VERSION ""

NS_ :

BS_:

BU_: DKY PSC MCR MCL PRG SRM AHL SMT TPM ACN EAM_HUD DAM BIU C_ECU C_ECU_GW

BO_ 1510 EAM5E6: 8 Vector__XXX

BO_ 1511 EAM5E7: 8 EAM_HUD
 SG_ EAM5E7_7_0_DATA : 7|64@0+ (1,0) [0|1.844674407371E+19] "" Vector__XXX

BO_ 552 RDR228: 8 C_ECU_GW
 SG_ RDR228_7_0_EYE_TIMEOUT_ERROR_FLG : 56|1@1+ (1,0) [0|1] "" Vector__XXX
 SG_ RDR228_7_1_BLOCKAGE_FORMING_2 : 57|1@1+ (1,0) [0|1] "" Vector__XXX
 SG_ RDR228_7_2_WARN_LCA_R_1ST : 58|1@1+ (1,0) [0|1] "" Vector__XXX
 SG_ RDR228_7_3_WARN_LCA_L_1ST : 59|1@1+ (1,0) [0|1] "" Vector__XXX
 SG_ RDR228_7_4_WARN_LCA_R_2ND : 60|1@1+ (1,0) [0|1] "" Vector__XXX
 SG_ RDR228_7_5_WARN_LCA_L_2ND : 61|1@1+ (1,0) [0|1] "" Vector__XXX
 SG_ RDR228_7_6_WARN_RCTA_R : 62|1@1+ (1,0) [0|1] "" Vector__XXX
 SG_ RDR228_7_7_WARN_RCTA_L : 63|1@1+ (1,0) [0|1] "" Vector__XXX
 SG_ RDR228_6_0_WARN_BSD_R_1ST : 48|1@1+ (1,0) [0|1] "" Vector__XXX
 SG_ RDR228_6_1_WARN_BSD_L_1ST : 49|1@1+ (1,0) [0|1] "" Vector__XXX
 SG_ RDR228_6_2_WARN_BSD_R_2ND : 50|1@1+ (1,0) [0|1] "" Vector__XXX
 SG_ RDR228_6_3_WARN_BSD_L_2ND : 51|1@1+ (1,0) [0|1] "" Vector__XXX
 SG_ RDR228_6_5_BLOCKAGE_STS : 53|3@1+ (1,0) [0|5] "" Vector__XXX
 SG_ RDR228_5_0_BSD_R_E : 40|1@1+ (1,0) [0|1] "" Vector__XXX
 SG_ RDR228_5_1_BSD_L_E : 41|1@1+ (1,0) [0|1] "" Vector__XXX
 SG_ RDR228_5_2_LCA_R_E : 42|1@1+ (1,0) [0|1] "" Vector__XXX
 SG_ RDR228_5_3_LCA_L_E : 43|1@1+ (1,0) [0|1] "" Vector__XXX
 SG_ RDR228_5_4_BSD_R_A : 44|1@1+ (1,0) [0|1] "" Vector__XXX
 SG_ RDR228_5_5_BSD_L_A : 45|1@1+ (1,0) [0|1] "" Vector__XXX
 SG_ RDR228_5_6_LCA_R_A : 46|1@1+ (1,0) [0|1] "" Vector__XXX
 SG_ RDR228_5_7_LCA_L_A : 47|1@1+ (1,0) [0|1] "" Vector__XXX
 SG_ RDR228_4_0_DOW_ACTIVELAMP : 32|1@1+ (1,0) [0|1] "" Vector__XXX
 SG_ RDR228_4_1_WARN_DOW_1ST_R : 33|1@1+ (1,0) [0|1] "" Vector__XXX
 SG_ RDR228_4_2_WARN_DOW_1ST_L : 34|1@1+ (1,0) [0|1] "" Vector__XXX
 SG_ RDR228_4_3_WARN_DOW_2ST_R : 35|1@1+ (1,0) [0|1] "" Vector__XXX
 SG_ RDR228_4_4_WARN_DOW_2ST_L : 36|1@1+ (1,0) [0|1] "" Vector__XXX
 SG_ RDR228_4_5_CSTM_STS_SRVD : 37|1@1+ (1,0) [0|1] "" Vector__XXX
 SG_ RDR228_4_6_CSTM_STS_BSD_LCA_2ND : 38|1@1+ (1,0) [0|1] "" Vector__XXX
 SG_ RDR228_4_7_CSTM_STS_RCTA : 39|1@1+ (1,0) [0|1] "" Vector__XXX
 SG_ RDR228_3_0_WARN_BSD_LCA_R_2ND : 24|1@1+ (1,0) [0|1] "" Vector__XXX
 SG_ RDR228_3_1_WARN_BSD_LCA_L_2ND : 25|1@1+ (1,0) [0|1] "" Vector__XXX
 SG_ RDR228_3_2_CSTM_STS_DOW : 26|1@1+ (1,0) [0|1] "" Vector__XXX
 SG_ RDR228_3_3_CSTM_STS_DOW_SFT_POS : 27|1@1+ (1,0) [0|1] "" Vector__XXX
 SG_ RDR228_3_5_CSTM_DSP_BSD_LCA : 29|1@1+ (1,0) [0|1] "" Vector__XXX
 SG_ RDR228_3_6_CSTM_DSP_BSD_LCA_2ND : 30|1@1+ (1,0) [0|1] "" Vector__XXX
 SG_ RDR228_3_7_CSTM_DSP_RCTA : 31|1@1+ (1,0) [0|1] "" Vector__XXX
 SG_ RDR228_2_0_CSTM_DSP_DOW : 16|1@1+ (1,0) [0|1] "" Vector__XXX
 SG_ RDR228_2_1_EYE_LOCAL_BUS1_FAIL : 17|1@1+ (1,0) [0|1] "" Vector__XXX
 SG_ RDR228_2_2_CSTM_DSP_DOW_SFT_POS : 18|1@1+ (1,0) [0|1] "" Vector__XXX
 SG_ RDR228_2_3_ELK_STOP_REQ_FLG : 19|1@1+ (1,0) [0|1] "" Vector__XXX
 SG_ RDR228_2_4_FAIL_RDRSYS : 20|1@1+ (1,0) [0|1] "" Vector__XXX
 SG_ RDR228_2_5_STOP_RDRSYS : 21|1@1+ (1,0) [0|1] "" Vector__XXX
 SG_ RDR228_2_6_ON_OFF_RDRSYS : 22|1@1+ (1,0) [0|1] "" Vector__XXX
 SG_ RDR228_2_7_BLOCKAGE_FORMING : 23|1@1+ (1,0) [0|1] "" Vector__XXX
 SG_ RDR228_1_0_MSG_COUNTER : 8|4@1+ (1,0) [0|15] "" Vector__XXX
 SG_ RDR228_1_4_BATT_OFF_CAUSE : 12|1@1+ (1,0) [0|1] "" Vector__XXX
 SG_ RDR228_1_5_CSTM_GLO_1 : 13|1@1+ (1,0) [0|1] "" Vector__XXX
 SG_ RDR228_1_6_CSTM_GLO_3 : 14|1@1+ (1,0) [0|1] "" Vector__XXX
 SG_ RDR228_1_7_CSTM_GLO_2 : 15|1@1+ (1,0) [0|1] "" Vector__XXX
 SG_ RDR228_0_0_CHECK_SUM : 0|8@1+ (1,0) [0|255] "" Vector__XXX

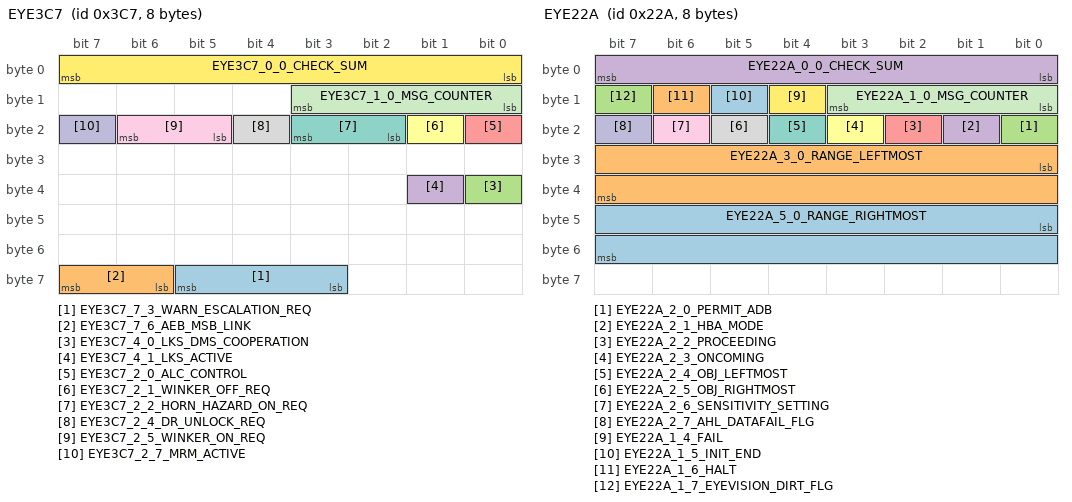
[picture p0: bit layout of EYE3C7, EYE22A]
BO_ 967 EYE3C7: 8 C_ECU_GW
 SG_ EYE3C7_7_3_WARN_ESCALATION_REQ : 59|3@1+ (1,0) [0|7] "" Vector__XXX
 SG_ EYE3C7_7_6_AEB_MSB_LINK : 62|2@1+ (1,0) [0|3] "" Vector__XXX
 SG_ EYE3C7_4_0_LKS_DMS_COOPERATION : 32|1@1+ (1,0) [0|1] "" Vector__XXX
 SG_ EYE3C7_4_1_LKS_ACTIVE : 33|1@1+ (1,0) [0|1] "" Vector__XXX
 SG_ EYE3C7_2_0_ALC_CONTROL : 16|1@1+ (1,0) [0|1] ""  BIU
 SG_ EYE3C7_2_1_WINKER_OFF_REQ : 17|1@1+ (1,0) [0|1] ""  BIU
 SG_ EYE3C7_2_2_HORN_HAZARD_ON_REQ : 18|2@1+ (1,0) [0|3] ""  BIU
 SG_ EYE3C7_2_4_DR_UNLOCK_REQ : 20|1@1+ (1,0) [0|1] ""  BIU
 SG_ EYE3C7_2_5_WINKER_ON_REQ : 21|2@1+ (1,0) [0|3] ""  BIU
 SG_ EYE3C7_2_7_MRM_ACTIVE : 23|1@1+ (1,0) [0|1] ""  BIU
 SG_ EYE3C7_1_0_MSG_COUNTER : 8|4@1+ (1,0) [0|15] ""  BIU
 SG_ EYE3C7_0_0_CHECK_SUM : 0|8@1+ (1,0) [0|255] ""  BIU

BO_ 964 EYE3C4: 8 C_ECU_GW
 SG_ EYE3C4_7_0_PCR_FAIL_OFF_IND : 56|2@1+ (1,0) [0|3] "" Vector__XXX
 SG_ EYE3C4_7_2_AES_FAIL_OFF_IND : 58|2@1+ (1,0) [0|3] "" Vector__XXX
 SG_ EYE3C4_7_4_LDP_FAIL_OFF_IND : 60|2@1+ (1,0) [0|3] "" Vector__XXX
 SG_ EYE3C4_7_6_ELK_FAIL_OFF_IND : 62|2@1+ (1,0) [0|3] "" Vector__XXX
 SG_ EYE3C4_6_0_MCAM_SYS_FAIL_HALT : 48|2@1+ (1,0) [0|3] "" Vector__XXX
 SG_ EYE3C4_6_2_MCAM_FUNC_INFO : 50|1@1+ (1,0) [0|1] "" Vector__XXX
 SG_ EYE3C4_6_3_EYE_DRV_ACTION_REQ : 51|3@1+ (1,0) [0|7] "" Vector__XXX
 SG_ EYE3C4_6_6_LDW_SND_OFF_FAIL_IND : 54|2@1+ (1,0) [0|3] "" Vector__XXX
 SG_ EYE3C4_5_0_EAM_GREEN : 40|2@1+ (1,0) [0|3] ""  EAM_HUD
 SG_ EYE3C4_5_2_EAM_BLUE : 42|2@1+ (1,0) [0|3] ""  EAM_HUD
 SG_ EYE3C4_5_4_EAM_GREEN_2 : 44|2@1+ (1,0) [0|3] ""  EAM_HUD
 SG_ EYE3C4_5_6_FCW_SND_OFF_FAIL_IND : 46|2@1+ (1,0) [0|3] "" Vector__XXX
 SG_ EYE3C4_4_0_EAM_YELLOW : 32|4@1+ (1,0) [0|15] ""  EAM_HUD
 SG_ EYE3C4_4_4_EAM_RED : 36|4@1+ (1,0) [0|15] ""  EAM_HUD
 SG_ EYE3C4_3_0_CODE_NO_BUZZER : 24|8@1+ (1,0) [0|255] "" Vector__XXX
 SG_ EYE3C4_2_0_CODE_WARN : 16|8@1+ (1,0) [0|255] "" Vector__XXX
 SG_ EYE3C4_1_0_MSG_COUNTER : 8|4@1+ (1,0) [0|15] ""  EAM_HUD
 SG_ EYE3C4_1_5_SNR_DRV_ACTION_REQ : 13|3@1+ (1,0) [0|7] "" Vector__XXX
 SG_ EYE3C4_0_0_CHECK_SUM : 0|8@1+ (1,0) [0|255] "" Vector__XXX

BO_ 554 EYE22A: 8 C_ECU_GW
 SG_ EYE22A_5_0_RANGE_RIGHTMOST : 40|16@1- (0.1,0) [-3276.8|3276.7] "deg"  AHL
 SG_ EYE22A_3_0_RANGE_LEFTMOST : 24|16@1- (0.1,0) [-3276.8|3276.7] "deg"  AHL
 SG_ EYE22A_2_0_PERMIT_ADB : 16|1@1+ (1,0) [0|1] ""  AHL
 SG_ EYE22A_2_1_HBA_MODE : 17|1@1+ (1,0) [0|1] "" Vector__XXX
 SG_ EYE22A_2_2_PROCEEDING : 18|1@1+ (1,0) [0|1] ""  AHL
 SG_ EYE22A_2_3_ONCOMING : 19|1@1+ (1,0) [0|1] ""  AHL
 SG_ EYE22A_2_4_OBJ_LEFTMOST : 20|1@1+ (1,0) [0|1] ""  AHL
 SG_ EYE22A_2_5_OBJ_RIGHTMOST : 21|1@1+ (1,0) [0|1] ""  AHL
 SG_ EYE22A_2_6_SENSITIVITY_SETTING : 22|1@1+ (1,0) [0|1] "" Vector__XXX
 SG_ EYE22A_2_7_AHL_DATAFAIL_FLG : 23|1@1+ (1,0) [0|1] ""  AHL
 SG_ EYE22A_1_0_MSG_COUNTER : 8|4@1+ (1,0) [0|15] ""  AHL,BIU
 SG_ EYE22A_1_4_FAIL : 12|1@1+ (1,0) [0|1] ""  AHL,BIU
 SG_ EYE22A_1_5_INIT_END : 13|1@1+ (1,0) [0|1] ""  AHL,BIU
 SG_ EYE22A_1_6_HALT : 14|1@1+ (1,0) [0|1] ""  BIU
 SG_ EYE22A_1_7_EYEVISION_DIRT_FLG : 15|1@1+ (1,0) [0|1] ""  BIU
 SG_ EYE22A_0_0_CHECK_SUM : 0|8@1+ (1,0) [0|255] ""  BIU

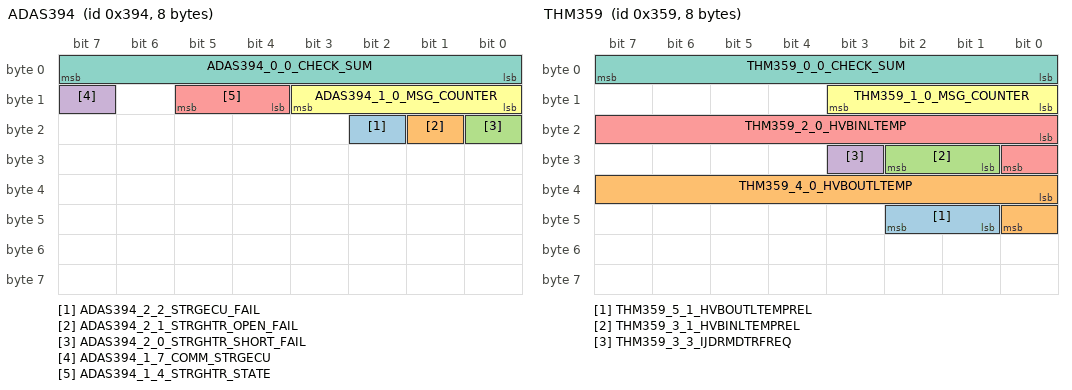
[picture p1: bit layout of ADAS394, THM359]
BO_ 916 ADAS394: 8 C_ECU_GW
 SG_ ADAS394_2_2_STRGECU_FAIL : 18|1@1+ (1,0) [0|1] ""  ACN
 SG_ ADAS394_2_1_STRGHTR_OPEN_FAIL : 17|1@1+ (1,0) [0|1] ""  ACN
 SG_ ADAS394_2_0_STRGHTR_SHORT_FAIL : 16|1@1+ (1,0) [0|1] ""  ACN
 SG_ ADAS394_1_7_COMM_STRGECU : 15|1@1+ (1,0) [0|1] ""  ACN
 SG_ ADAS394_1_4_STRGHTR_STATE : 12|2@1+ (1,0) [0|3] ""  ACN
 SG_ ADAS394_1_0_MSG_COUNTER : 8|4@1+ (1,0) [0|15] ""  ACN
 SG_ ADAS394_0_0_CHECK_SUM : 0|8@1+ (1,0) [0|255] ""  ACN

BO_ 857 THM359: 8 C_ECU_GW
 SG_ THM359_5_1_HVBOUTLTEMPREL : 41|2@1+ (1,0) [0|3] ""  ACN
 SG_ THM359_4_0_HVBOUTLTEMP : 32|9@1+ (0.5,-40) [-40|215.5] "℃"  ACN
 SG_ THM359_3_1_HVBINLTEMPREL : 25|2@1+ (1,0) [0|3] ""  ACN
 SG_ THM359_3_3_IJDRMDTRFREQ : 27|1@1+ (1,0) [0|1] ""  ACN
 SG_ THM359_2_0_HVBINLTEMP : 16|9@1+ (0.5,-40) [-40|215.5] "℃"  ACN
 SG_ THM359_1_0_MSG_COUNTER : 8|4@1+ (1,0) [0|15] ""  ACN
 SG_ THM359_0_0_CHECK_SUM : 0|8@1+ (1,0) [0|255] ""  ACN

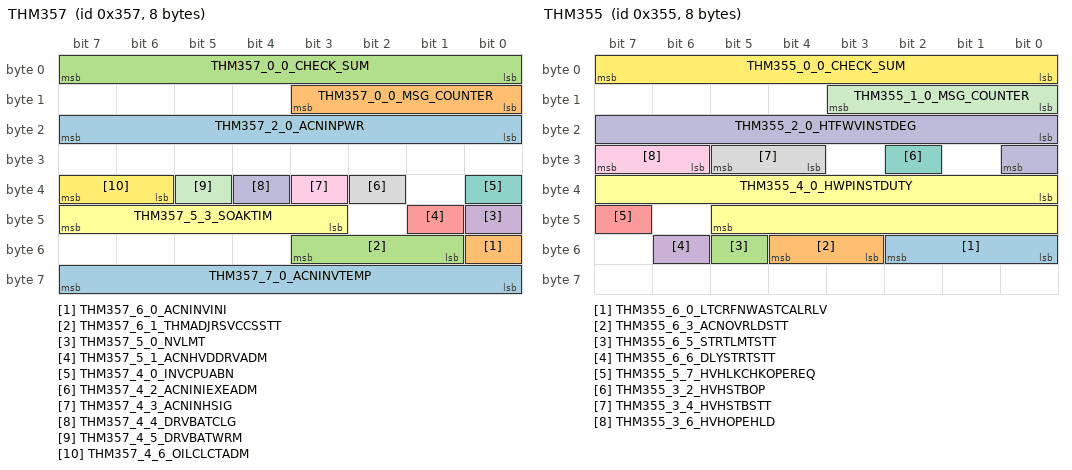
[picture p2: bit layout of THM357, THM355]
BO_ 855 THM357: 8 C_ECU_GW
 SG_ THM357_7_0_ACNINVTEMP : 56|8@1+ (1,-60) [-60|195] "℃"  ACN
 SG_ THM357_6_0_ACNINVINI : 48|1@1+ (1,0) [0|1] ""  ACN
 SG_ THM357_6_1_THMADJRSVCCSSTT : 49|3@1+ (1,0) [0|7] ""  ACN
 SG_ THM357_5_0_NVLMT : 40|1@1+ (1,0) [0|1] ""  ACN
 SG_ THM357_5_1_ACNHVDDRVADM : 41|1@1+ (1,0) [0|1] ""  ACN
 SG_ THM357_5_3_SOAKTIM : 43|5@1+ (1,0) [0|31] "Hr"  ACN
 SG_ THM357_4_0_INVCPUABN : 32|1@1+ (1,0) [0|1] ""  ACN
 SG_ THM357_4_2_ACNINIEXEADM : 34|1@1+ (1,0) [0|1] ""  ACN
 SG_ THM357_4_3_ACNINHSIG : 35|1@1+ (1,0) [0|1] ""  ACN
 SG_ THM357_4_4_DRVBATCLG : 36|1@1+ (1,0) [0|1] ""  ACN
 SG_ THM357_4_5_DRVBATWRM : 37|1@1+ (1,0) [0|1] ""  ACN
 SG_ THM357_4_6_OILCLCTADM : 38|2@1+ (1,0) [0|3] ""  ACN
 SG_ THM357_2_0_ACNINPWR : 16|8@1+ (50,0) [0|12750] "W"  ACN
 SG_ THM357_0_0_MSG_COUNTER : 8|4@1+ (1,0) [0|15] ""  ACN
 SG_ THM357_0_0_CHECK_SUM : 0|8@1+ (1,0) [0|255] ""  ACN

BO_ 854 THM356: 8 C_ECU_GW
 SG_ THM356_7_0_INVTEMPSNSABN : 56|1@1+ (1,0) [0|1] ""  ACN
 SG_ THM356_7_1_STBSTT : 57|1@1+ (1,0) [0|1] ""  ACN
 SG_ THM356_7_2_INVINTERR : 58|2@1+ (1,0) [0|3] ""  ACN
 SG_ THM356_7_4_SELFINVCHK : 60|1@1+ (1,0) [0|1] ""  ACN
 SG_ THM356_7_5_INVINTPWRABN : 61|2@1+ (1,0) [0|3] ""  ACN
 SG_ THM356_6_0_INVCURSNSABN : 48|1@1+ (1,0) [0|1] ""  ACN
 SG_ THM356_6_1_ACNMOTCTRLABN : 49|2@1+ (1,0) [0|3] ""  ACN
 SG_ THM356_6_3_ACNCMNSTT_INV : 51|1@1+ (1,0) [0|1] ""  ACN
 SG_ THM356_6_4_CMPSTT : 52|3@1+ (1,0) [0|7] ""  ACN
 SG_ THM356_6_7_RESLOTEMPABN : 55|1@1+ (1,0) [0|1] ""  ACN
 SG_ THM356_5_2_FRCDAIRCYCLREQ : 42|1@1+ (1,0) [0|1] ""  ACN
 SG_ THM356_5_3_ACNCMNSTT_ICU : 43|1@1+ (1,0) [0|1] ""  ACN
 SG_ THM356_5_4_INVMAINVLTDIAG : 44|2@1+ (1,0) [0|3] ""  ACN
 SG_ THM356_5_6_INVOVRHEAT : 46|2@1+ (1,0) [0|3] ""  ACN
 SG_ THM356_4_0_ACNSYSADMPWR : 32|10@1+ (50,0) [0|17400] "W"  ACN
 SG_ THM356_2_0_ACNMOTSPD : 16|16@1+ (1,0) [0|65535] "rpm"  ACN
 SG_ THM356_1_0_MSG_COUNTER : 8|4@1+ (1,0) [0|15] ""  ACN
 SG_ THM356_0_0_CHECK_SUM : 0|8@1+ (1,0) [0|255] ""  ACN

BO_ 853 THM355: 8 C_ECU_GW
 SG_ THM355_6_0_LTCRFNWASTCALRLV : 48|3@1+ (1,0) [0|7] ""  ACN
 SG_ THM355_6_3_ACNOVRLDSTT : 51|2@1+ (1,0) [0|3] ""  ACN
 SG_ THM355_6_5_STRTLMTSTT : 53|1@1+ (1,0) [0|1] ""  ACN
 SG_ THM355_6_6_DLYSTRTSTT : 54|1@1+ (1,0) [0|1] ""  ACN
 SG_ THM355_5_7_HVHLKCHKOPEREQ : 47|1@1+ (1,0) [0|1] ""  ACN
 SG_ THM355_4_0_HWPINSTDUTY : 32|14@1+ (0.006103515625,0) [0|100] "%"  ACN
 SG_ THM355_3_2_HVHSTBOP : 26|1@1+ (1,0) [0|1] ""  ACN
 SG_ THM355_3_4_HVHSTBSTT : 28|2@1+ (1,0) [0|3] ""  ACN
 SG_ THM355_3_6_HVHOPEHLD : 30|2@1+ (1,0) [0|3] ""  ACN
 SG_ THM355_2_0_HTFWVINSTDEG : 16|9@1+ (1,0) [0|360] "deg"  ACN
 SG_ THM355_1_0_MSG_COUNTER : 8|4@1+ (1,0) [0|15] ""  ACN
 SG_ THM355_0_0_CHECK_SUM : 0|8@1+ (1,0) [0|255] ""  ACN

BO_ 852 THM354: 8 C_ECU_GW
 SG_ THM354_7_0_HVHCLTPHI : 56|1@1+ (1,0) [0|1] ""  ACN
 SG_ THM354_7_5_HVHOVHTSTT : 61|1@1+ (1,0) [0|1] ""  ACN
 SG_ THM354_7_7_HVHINTCMNABN : 63|1@1+ (1,0) [0|1] ""  ACN
 SG_ THM354_6_0_HVHVLT : 48|8@1+ (0.1,0) [0|25.5] "V"  ACN
 SG_ THM354_5_0_HVHACTCNSPCUR : 40|8@1+ (0.25,0) [0|63.75] "A"  ACN
 SG_ THM354_4_0_HVHINLCLTP : 32|8@1+ (1,-40) [-40|215] "℃"  ACN
 SG_ THM354_3_0_HVHOUTLCLTP : 24|8@1+ (1,-40) [-40|215] "℃"  ACN
 SG_ THM354_2_0_HVHIGBTABN : 16|1@1+ (1,0) [0|1] ""  ACN
 SG_ THM354_2_1_HVHSTBSTT : 17|2@1+ (1,0) [0|3] ""  ACN
 SG_ THM354_2_3_HVHMEMABN : 19|1@1+ (1,0) [0|1] ""  ACN
 SG_ THM354_2_4_HVHSERVREQ : 20|1@1+ (1,0) [0|1] ""  ACN
 SG_ THM354_2_5_HVHSTTFBK : 21|3@1+ (1,0) [0|7] ""  ACN
 SG_ THM354_1_0_MSG_COUNTER : 8|4@1+ (1,0) [0|15] ""  ACN
 SG_ THM354_1_4_HVHINLCLTPABN : 12|1@1+ (1,0) [0|1] ""  ACN
 SG_ THM354_1_5_HVHOUTLCLTPABN : 13|1@1+ (1,0) [0|1] ""  ACN
 SG_ THM354_1_6_HVHOVHTABN : 14|1@1+ (1,0) [0|1] ""  ACN
 SG_ THM354_1_7_HVHLINABN : 15|1@1+ (1,0) [0|1] ""  ACN
 SG_ THM354_0_0_CHECK_SUM : 0|8@1+ (1,0) [0|255] ""  ACN

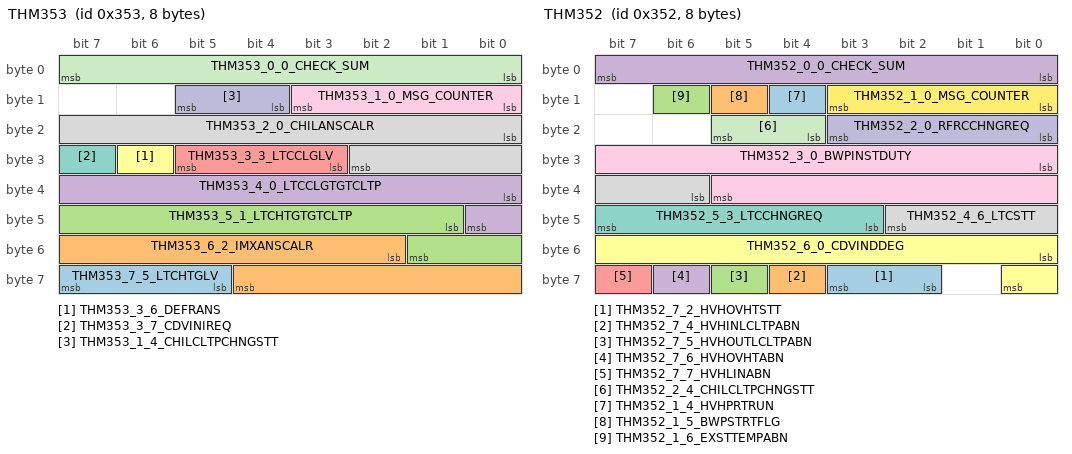
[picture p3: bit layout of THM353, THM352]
BO_ 851 THM353: 8 C_ECU_GW
 SG_ THM353_7_5_LTCHTGLV : 61|3@1+ (1,0) [0|7] ""  ACN
 SG_ THM353_6_2_IMXANSCALR : 50|11@1+ (10,0) [0|20470] "W"  ACN
 SG_ THM353_5_1_LTCHTGTGTCLTP : 41|9@1+ (0.5,-40) [-40|215.5] "℃"  ACN
 SG_ THM353_4_0_LTCCLGTGTCLTP : 32|9@1+ (0.5,-40) [-40|215.5] "℃"  ACN
 SG_ THM353_3_3_LTCCLGLV : 27|3@1+ (1,0) [0|7] ""  ACN
 SG_ THM353_3_6_DEFRANS : 30|1@1+ (1,0) [0|1] ""  ACN
 SG_ THM353_3_7_CDVINIREQ : 31|1@1+ (1,0) [0|1] ""  ACN
 SG_ THM353_2_0_CHILANSCALR : 16|11@1+ (10,0) [0|20470] "W"  ACN
 SG_ THM353_1_0_MSG_COUNTER : 8|4@1+ (1,0) [0|15] ""  ACN
 SG_ THM353_1_4_CHILCLTPCHNGSTT : 12|2@1+ (1,0) [0|3] ""  ACN
 SG_ THM353_0_0_CHECK_SUM : 0|8@1+ (1,0) [0|255] ""  ACN

BO_ 850 THM352: 8 C_ECU_GW
 SG_ THM352_7_2_HVHOVHTSTT : 58|2@1+ (1,0) [0|1] ""  ACN
 SG_ THM352_7_4_HVHINLCLTPABN : 60|1@1+ (1,0) [0|1] ""  ACN
 SG_ THM352_7_5_HVHOUTLCLTPABN : 61|1@1+ (1,0) [0|1] ""  ACN
 SG_ THM352_7_6_HVHOVHTABN : 62|1@1+ (1,0) [0|1] ""  ACN
 SG_ THM352_7_7_HVHLINABN : 63|1@1+ (1,0) [0|1] ""  ACN
 SG_ THM352_6_0_CDVINDDEG : 48|9@1+ (1,0) [0|360] "deg"  ACN
 SG_ THM352_5_3_LTCCHNGREQ : 43|5@1+ (1,0) [0|13] ""  ACN
 SG_ THM352_4_6_LTCSTT : 38|5@1+ (1,0) [0|13] ""  ACN
 SG_ THM352_3_0_BWPINSTDUTY : 24|14@1+ (0.006103515625,0) [0|100] "%"  ACN
 SG_ THM352_2_0_RFRCCHNGREQ : 16|4@1+ (1,0) [0|8] ""  ACN
 SG_ THM352_2_4_CHILCLTPCHNGSTT : 20|2@1+ (1,0) [0|3] ""  ACN
 SG_ THM352_1_0_MSG_COUNTER : 8|4@1+ (1,0) [0|15] ""  ACN
 SG_ THM352_1_4_HVHPRTRUN : 12|1@1+ (1,0) [0|1] ""  ACN
 SG_ THM352_1_5_BWPSTRTFLG : 13|1@1+ (1,0) [0|1] ""  ACN
 SG_ THM352_1_6_EXSTTEMPABN : 14|1@1+ (1,0) [0|1] ""  ACN
 SG_ THM352_0_0_CHECK_SUM : 0|8@1+ (1,0) [0|255] ""  ACN

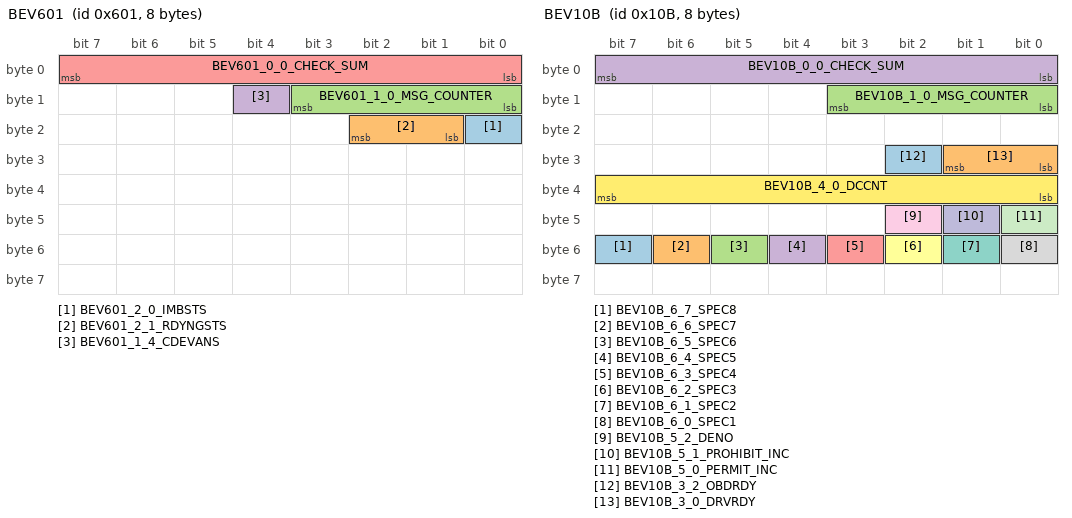
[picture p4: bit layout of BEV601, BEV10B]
BO_ 1537 BEV601: 8 C_ECU_GW
 SG_ BEV601_2_0_IMBSTS : 16|1@1+ (1,0) [0|1] ""  BIU
 SG_ BEV601_2_1_RDYNGSTS : 17|2@1+ (1,0) [0|3] ""  SMT
 SG_ BEV601_1_0_MSG_COUNTER : 8|4@1+ (1,0) [0|15] ""  SMT,BIU
 SG_ BEV601_1_4_CDEVANS : 12|1@1+ (1,0) [0|1] "" Vector__XXX
 SG_ BEV601_0_0_CHECK_SUM : 0|8@1+ (1,0) [0|255] ""  SMT,BIU

BO_ 267 BEV10B: 8 C_ECU_GW
 SG_ BEV10B_6_7_SPEC8 : 55|1@1+ (1,0) [0|1] "" Vector__XXX
 SG_ BEV10B_6_6_SPEC7 : 54|1@1+ (1,0) [0|1] "" Vector__XXX
 SG_ BEV10B_6_5_SPEC6 : 53|1@1+ (1,0) [0|1] "" Vector__XXX
 SG_ BEV10B_6_4_SPEC5 : 52|1@1+ (1,0) [0|1] "" Vector__XXX
 SG_ BEV10B_6_3_SPEC4 : 51|1@1+ (1,0) [0|1] "" Vector__XXX
 SG_ BEV10B_6_2_SPEC3 : 50|1@1+ (1,0) [0|1] "" Vector__XXX
 SG_ BEV10B_6_1_SPEC2 : 49|1@1+ (1,0) [0|1] "" Vector__XXX
 SG_ BEV10B_6_0_SPEC1 : 48|1@1+ (1,0) [0|1] "" Vector__XXX
 SG_ BEV10B_5_2_DENO : 42|1@1+ (1,0) [0|1] "" Vector__XXX
 SG_ BEV10B_5_1_PROHIBIT_INC : 41|1@1+ (1,0) [0|1] "" Vector__XXX
 SG_ BEV10B_5_0_PERMIT_INC : 40|1@1+ (1,0) [0|1] "" Vector__XXX
 SG_ BEV10B_4_0_DCCNT : 32|8@1+ (1,0) [0|255] ""  ACN
 SG_ BEV10B_3_2_OBDRDY : 26|1@1+ (1,0) [0|1] ""  ACN
 SG_ BEV10B_3_0_DRVRDY : 24|2@1+ (1,0) [0|3] "" Vector__XXX
 SG_ BEV10B_1_0_MSG_COUNTER : 8|4@1+ (1,0) [0|15] ""  ACN
 SG_ BEV10B_0_0_CHECK_SUM : 0|8@1+ (1,0) [0|255] ""  ACN

BO_ 116 BEV074: 8 C_ECU_GW
 SG_ BEV074_7_0_LVPWRDWN : 56|6@1+ (1,0) [0|3] ""  ACN
 SG_ BEV074_7_6_CHRCONSTA : 62|1@1+ (1,0) [0|1] ""  SMT
 SG_ BEV074_7_7_VEHICLE_IGN : 63|1@1+ (1,0) [0|1] ""  TPM,EAM_HUD,BIU
 SG_ BEV074_6_0_EV_CAU : 48|2@1+ (1,0) [0|3] "" Vector__XXX
 SG_ BEV074_6_2_BEV_OBD_CAU : 50|3@1+ (1,0) [0|7] "" Vector__XXX
 SG_ BEV074_6_5_SIDRIVE_DISP : 53|3@1+ (1,0) [0|7] ""  BIU
 SG_ BEV074_5_0_ACCHG_STATE : 40|1@1+ (1,0) [0|1] ""  ACN
 SG_ BEV074_5_1_DCCHG_STATE : 41|1@1+ (1,0) [0|1] ""  ACN
 SG_ BEV074_5_2_RANGE_DG : 42|1@1+ (1,0) [0|1] "" Vector__XXX
 SG_ BEV074_5_3_ACCP_DG : 43|1@1+ (1,0) [0|1] "" Vector__XXX
 SG_ BEV074_5_4_REZ_SPD_BK : 44|2@1+ (1,0) [0|3] "" Vector__XXX
 SG_ BEV074_5_6_OBDRDY : 46|1@1+ (1,0) [0|1] "" Vector__XXX
 SG_ BEV074_5_7_FHVB : 47|1@1+ (1,0) [0|1] ""  SMT
 SG_ BEV074_3_0_RANGE_POS : 24|3@1+ (1,0) [0|7] ""  DKY,SRM,AHL,SMT,TPM,BIU
 SG_ BEV074_3_3_DRVRDY : 27|2@1+ (1,0) [0|3] ""  DKY,SMT,ACN
 SG_ BEV074_3_5_HVSYSTS : 29|2@1+ (1,0) [0|3] "" Vector__XXX
 SG_ BEV074_3_7_REZ_SPD_GL : 31|9@1- (1,0) [-256|255] "km/h" Vector__XXX
 SG_ BEV074_2_0_ACCP_USR : 16|8@1+ (0.5,0) [0|127.5] "%" Vector__XXX
 SG_ BEV074_1_0_MSG_COUNTER : 8|4@1+ (1,0) [0|15] ""  SMT,ACN
 SG_ BEV074_1_4_RANGE_DG2 : 12|1@1+ (1,0) [0|1] "" Vector__XXX
 SG_ BEV074_1_5_REZ_SPD_BK : 13|3@1+ (1,0) [0|5] "" Vector__XXX
 SG_ BEV074_0_0_CHECK_SUM : 0|8@1+ (1,0) [0|255] ""  SMT,ACN

BO_ 2564481103 PSM18DAE04F: 8 PSC
 SG_ PSM18DAE04F_DIAG_DATA : 7|64@0+ (1,0) [0|1.844674407371E+19] ""  C_ECU_GW

BO_ 2564444128 DNT18DA4FE0: 8 C_ECU_GW
 SG_ DNT18DA4FE0_DIAG_DATA : 7|64@0+ (1,0) [0|1.844674407371E+19] ""  PSC

BO_ 2564481205 MEP18DAE0B5: 8 MCR
 SG_ MEP18DAE0B5_DIAG_DATA : 7|64@0+ (1,0) [0|1.844674407371E+19] ""  C_ECU_GW

BO_ 2564470240 DNT18DAB5E0: 8 C_ECU_GW
 SG_ DNT18DAB5E0_DIAG_DATA : 7|64@0+ (1,0) [0|1.844674407371E+19] ""  MCR

BO_ 2564481204 MED18DAE0B4: 8 MCL
 SG_ MED18DAE0B4_DIAG_DATA : 7|64@0+ (1,0) [0|1.844674407371E+19] ""  C_ECU_GW

BO_ 2564469984 DNT18DAB4E0: 8 C_ECU_GW
 SG_ DNT18DAB4E0_DIAG_DATA : 7|64@0+ (1,0) [0|1.844674407371E+19] ""  MCL

BO_ 2564481150 PRG18DAE07E: 8 PRG
 SG_ PRG18DAE07E_DIAG_DATA : 7|64@0+ (1,0) [0|1.844674407371E+19] ""  C_ECU_GW

BO_ 2564456160 DNT18DA7EE0: 8 C_ECU_GW
 SG_ DNT18DA7EE0_DIAG_DATA : 7|64@0+ (1,0) [0|1.844674407371E+19] ""  PRG

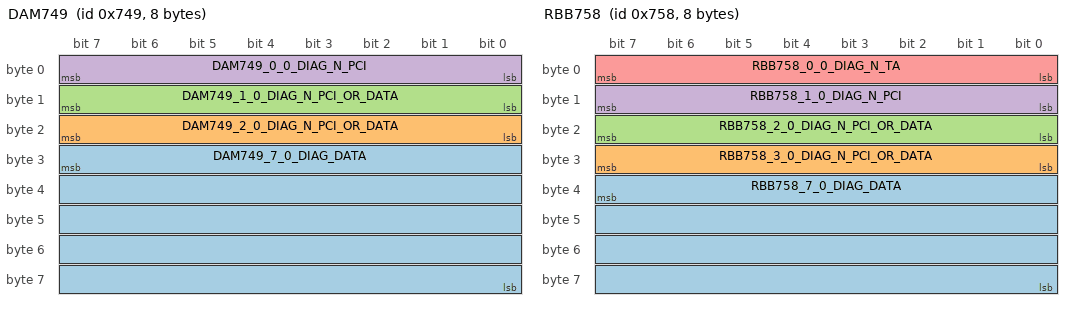
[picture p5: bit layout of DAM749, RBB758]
BO_ 1865 DAM749: 8 DAM
 SG_ DAM749_7_0_DIAG_DATA : 31|40@0+ (1,0) [0|1099511627775] ""  C_ECU_GW
 SG_ DAM749_2_0_DIAG_N_PCI_OR_DATA : 23|8@0+ (1,0) [0|255] ""  C_ECU_GW
 SG_ DAM749_1_0_DIAG_N_PCI_OR_DATA : 15|8@0+ (1,0) [0|255] ""  C_ECU_GW
 SG_ DAM749_0_0_DIAG_N_PCI : 7|8@0+ (1,0) [0|255] ""  C_ECU_GW

BO_ 1857 DNT741: 8 C_ECU_GW
 SG_ DNT741_7_0_DIAG_DATA : 31|40@0+ (1,0) [0|1099511627775] ""  DAM
 SG_ DNT741_2_0_DIAG_N_PCI_OR_DATA : 23|8@0+ (1,0) [0|255] ""  DAM
 SG_ DNT741_1_0_DIAG_N_PCI_OR_DATA : 15|8@0+ (1,0) [0|255] ""  DAM
 SG_ DNT741_0_0_DIAG_N_PCI : 7|8@0+ (1,0) [0|255] ""  DAM

BO_ 1851 EAM73B: 8 EAM_HUD
 SG_ EAM73B_7_0_DIAG_DATA : 31|40@0+ (1,0) [0|1099511627775] ""  C_ECU_GW
 SG_ EAM73B_2_0_DIAG_N_PCI_OR_DATA : 23|8@0+ (1,0) [0|255] ""  C_ECU_GW
 SG_ EAM73B_1_0_DIAG_N_PCI_OR_DATA : 15|8@0+ (1,0) [0|255] ""  C_ECU_GW
 SG_ EAM73B_0_0_DIAG_N_PCI : 7|8@0+ (1,0) [0|255] ""  C_ECU_GW

BO_ 1843 DNT733: 8 C_ECU_GW
 SG_ DNT733_7_0_DIAG_DATA : 31|40@0+ (1,0) [0|1099511627775] ""  EAM_HUD
 SG_ DNT733_2_0_DIAG_N_PCI_OR_DATA : 23|8@0+ (1,0) [0|255] ""  EAM_HUD
 SG_ DNT733_1_0_DIAG_N_PCI_OR_DATA : 15|8@0+ (1,0) [0|255] ""  EAM_HUD
 SG_ DNT733_0_0_DIAG_N_PCI : 7|8@0+ (1,0) [0|255] ""  EAM_HUD

BO_ 2564481214 RKE18DAE0BE: 8 Vector__XXX
 SG_ RKE18DAE0BE_DIAG_DATA : 7|64@0+ (1,0) [0|1.844674407371E+19] ""  C_ECU_GW

BO_ 2564472544 DNT18DABEE0: 8 C_ECU_GW
 SG_ DNT18DABEE0_DIAG_DATA : 7|64@0+ (1,0) [0|1.844674407371E+19] "" Vector__XXX

BO_ 2564481090 AHL18DAE042: 8 AHL
 SG_ AHL18DAE042_DIAG_DATA : 7|64@0+ (1,0) [0|1.844674407371E+19] ""  C_ECU_GW

BO_ 2564440800 DNT18DA42E0: 8 C_ECU_GW
 SG_ DNT18DA42E0_DIAG_DATA : 7|64@0+ (1,0) [0|1.844674407371E+19] ""  AHL

BO_ 2564468769 BIU18DAB021: 8 BIU
 SG_ BIU18DAB021_DIAG_DATA : 7|64@0+ (1,0) [0|1.844674407371E+19] ""  C_ECU_GW

BO_ 2564432304 AVN18DA21B0: 8 C_ECU_GW
 SG_ AVN18DA21B0_DIAG_DATA : 7|64@0+ (1,0) [0|1.844674407371E+19] ""  BIU

BO_ 2564481142 TPM18DAE076: 8 TPM
 SG_ TPM18DAE076_DIAG_DATA : 7|64@0+ (1,0) [0|1.844674407371E+19] ""  C_ECU_GW

BO_ 2564454112 DNT18DA76E0: 8 C_ECU_GW
 SG_ DNT18DA76E0_DIAG_DATA : 7|64@0+ (1,0) [0|1.844674407371E+19] ""  TPM

BO_ 2564481057 BIU18DAE021: 8 BIU
 SG_ BIU18DAE021_DIAG_DATA : 7|64@0+ (1,0) [0|1.844674407371E+19] ""  C_ECU_GW

BO_ 2564432352 DNT18DA21E0: 8 C_ECU_GW
 SG_ DNT18DA21E0_DIAG_DATA : 7|64@0+ (1,0) [0|1.844674407371E+19] ""  BIU

BO_ 1993 PMN7C9: 8 SMT
 SG_ PMN7C9_7_0_DIAG_DATA : 31|40@0+ (1,0) [0|1099511627775] ""  C_ECU_GW
 SG_ PMN7C9_2_0_DIAG_N_PCI_OR_DATA : 23|8@0+ (1,0) [0|255] ""  C_ECU_GW
 SG_ PMN7C9_1_0_DIAG_N_PCI_OR_DATA : 15|8@0+ (1,0) [0|255] ""  C_ECU_GW
 SG_ PMN7C9_0_0_DIAG_N_PCI : 7|8@0+ (1,0) [0|255] ""  C_ECU_GW

BO_ 1985 DNT7C1: 8 C_ECU_GW
 SG_ DNT7C1_7_0_DIAG_DATA : 31|40@0+ (1,0) [0|1099511627775] ""  SMT
 SG_ DNT7C1_2_0_DIAG_N_PCI_OR_DATA : 23|8@0+ (1,0) [0|255] ""  SMT
 SG_ DNT7C1_1_0_DIAG_N_PCI_OR_DATA : 15|8@0+ (1,0) [0|255] ""  SMT
 SG_ DNT7C1_0_0_DIAG_N_PCI : 7|8@0+ (1,0) [0|255] ""  SMT

BO_ 1980 SMT7BC: 8 SMT
 SG_ SMT7BC_7_0_DIAG_DATA : 31|40@0+ (1,0) [0|1099511627775] ""  C_ECU_GW
 SG_ SMT7BC_2_0_DIAG_N_PCI_OR_DATA : 23|8@0+ (1,0) [0|255] ""  C_ECU_GW
 SG_ SMT7BC_1_0_DIAG_N_PCI_OR_DATA : 15|8@0+ (1,0) [0|255] ""  C_ECU_GW
 SG_ SMT7BC_0_0_DIAG_N_PCI : 7|8@0+ (1,0) [0|255] ""  C_ECU_GW

BO_ 1972 DNT7B4: 8 C_ECU_GW
 SG_ DNT7B4_7_0_DIAG_DATA : 31|40@0+ (1,0) [0|1099511627775] ""  SMT
 SG_ DNT7B4_2_0_DIAG_N_PCI_OR_DATA : 23|8@0+ (1,0) [0|255] ""  SMT
 SG_ DNT7B4_1_0_DIAG_N_PCI_OR_DATA : 15|8@0+ (1,0) [0|255] ""  SMT
 SG_ DNT7B4_0_0_DIAG_N_PCI : 7|8@0+ (1,0) [0|255] ""  SMT

BO_ 2564502513 DNT18DB33F1: 8 C_ECU_GW
 SG_ DNT18DB33F1_DIAG_DATA : 7|64@0+ (1,0) [0|1.844674407371E+19] ""  ACN

BO_ 2564485528 ACN18DAF198: 8 ACN
 SG_ ACN18DAF198_DIAG_DATA : 7|64@0+ (1,0) [0|1.844674407371E+19] ""  C_ECU_GW

BO_ 2564462833 DNT18DA98F1: 8 C_ECU_GW
 SG_ DNT18DA98F1_DIAG_DATA : 7|64@0+ (1,0) [0|1.844674407371E+19] ""  ACN

BO_ 2564481176 ACN18DAE098: 8 ACN
 SG_ ACN18DAE098_DIAG_DATA : 7|64@0+ (1,0) [0|1.844674407371E+19] ""  C_ECU_GW

BO_ 2564462816 DNT18DA98E0: 8 C_ECU_GW
 SG_ DNT18DA98E0_DIAG_DATA : 7|64@0+ (1,0) [0|1.844674407371E+19] ""  ACN

BO_ 1919 ACN77F: 8 ACN
 SG_ ACN77F_7_0_DIAG_DATA : 31|40@0+ (1,0) [0|1099511627775] ""  C_ECU_GW
 SG_ ACN77F_2_0_DIAG_N_PCI_OR_DATA : 23|8@0+ (1,0) [0|255] ""  C_ECU_GW
 SG_ ACN77F_1_0_DIAG_N_PCI_OR_DATA : 15|8@0+ (1,0) [0|255] ""  C_ECU_GW
 SG_ ACN77F_0_0_DIAG_N_PCI : 7|8@0+ (1,0) [0|255] ""  C_ECU_GW

BO_ 1911 DNT777: 8 C_ECU_GW
 SG_ DNT777_7_0_DIAG_DATA : 31|40@0+ (1,0) [0|1099511627775] ""  ACN
 SG_ DNT777_2_0_DIAG_N_PCI_OR_DATA : 23|8@0+ (1,0) [0|255] ""  ACN
 SG_ DNT777_1_0_DIAG_N_PCI_OR_DATA : 15|8@0+ (1,0) [0|255] ""  ACN
 SG_ DNT777_0_0_DIAG_N_PCI : 7|8@0+ (1,0) [0|255] ""  ACN

BO_ 1996 ACN7CC: 8 ACN
 SG_ ACN7CC_7_0_DIAG_DATA : 31|40@0+ (1,0) [0|1099511627775] ""  C_ECU_GW
 SG_ ACN7CC_2_0_DIAG_N_PCI_OR_DATA : 23|8@0+ (1,0) [0|255] ""  C_ECU_GW
 SG_ ACN7CC_1_0_DIAG_N_PCI_OR_DATA : 15|8@0+ (1,0) [0|255] ""  C_ECU_GW
 SG_ ACN7CC_0_0_DIAG_N_PCI : 7|8@0+ (1,0) [0|255] ""  C_ECU_GW

BO_ 1988 DNT7C4: 8 C_ECU_GW
 SG_ DNT7C4_7_0_DIAG_DATA : 31|40@0+ (1,0) [0|1099511627775] ""  ACN
 SG_ DNT7C4_2_0_DIAG_N_PCI_OR_DATA : 23|8@0+ (1,0) [0|255] ""  ACN
 SG_ DNT7C4_1_0_DIAG_N_PCI_OR_DATA : 15|8@0+ (1,0) [0|255] ""  ACN
 SG_ DNT7C4_0_0_DIAG_N_PCI : 7|8@0+ (1,0) [0|255] ""  ACN

BO_ 2564550625 CECU18DBEFE1: 8 C_ECU
 SG_ CECU18DBEFE1_DIAG_DATA : 7|64@0+ (1,0) [0|1.844674407371E+19] ""  PRG,AHL,EAM_HUD,DAM,BIU

BO_ 2564550624 DNT18DBEFE0: 8 C_ECU_GW
 SG_ DNT18DBEFE0_DIAG_DATA : 7|64@0+ (1,0) [0|1.844674407371E+19] ""  PSC,MCR,MCL,PRG,AHL,TPM,ACN,BIU

BO_ 1832 DNT728: 8 C_ECU_GW
 SG_ DNT728_7_0_DIAG_DATA : 31|40@0+ (1,0) [0|1099511627775] ""  SMT,ACN,DAM
 SG_ DNT728_2_0_DIAG_N_PCI_OR_DATA : 23|8@0+ (1,0) [0|255] ""  SMT,ACN,DAM
 SG_ DNT728_1_0_DIAG_N_PCI_OR_DATA : 15|8@0+ (1,0) [0|255] ""  SMT,ACN,DAM
 SG_ DNT728_0_0_DIAG_N_PCI : 7|8@0+ (1,0) [0|255] ""  SMT,ACN,DAM

BO_ 1880 RBB758: 8 BIU
 SG_ RBB758_7_0_DIAG_DATA : 39|32@0+ (1,0) [0|4294967295] ""  C_ECU_GW
 SG_ RBB758_3_0_DIAG_N_PCI_OR_DATA : 31|8@0+ (1,0) [0|255] ""  C_ECU_GW
 SG_ RBB758_2_0_DIAG_N_PCI_OR_DATA : 23|8@0+ (1,0) [0|255] ""  C_ECU_GW
 SG_ RBB758_1_0_DIAG_N_PCI : 15|8@0+ (1,0) [0|255] ""  C_ECU_GW
 SG_ RBB758_0_0_DIAG_N_TA : 7|8@0+ (1,0) [0|236] ""  C_ECU_GW

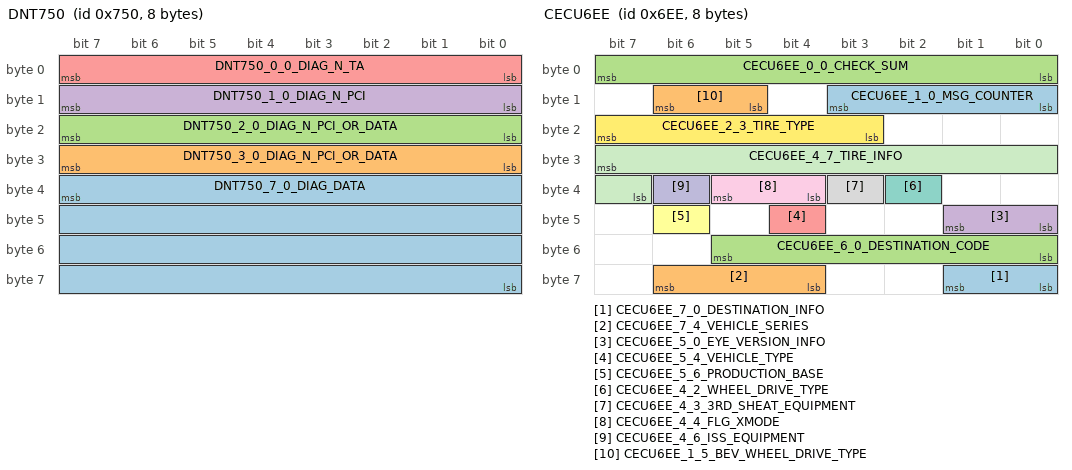
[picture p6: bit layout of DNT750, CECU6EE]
BO_ 1872 DNT750: 8 C_ECU_GW
 SG_ DNT750_7_0_DIAG_DATA : 39|32@0+ (1,0) [0|4294967295] ""  BIU
 SG_ DNT750_3_0_DIAG_N_PCI_OR_DATA : 31|8@0+ (1,0) [0|255] ""  BIU
 SG_ DNT750_2_0_DIAG_N_PCI_OR_DATA : 23|8@0+ (1,0) [0|255] ""  BIU
 SG_ DNT750_1_0_DIAG_N_PCI : 15|8@0+ (1,0) [0|255] ""  BIU
 SG_ DNT750_0_0_DIAG_N_TA : 7|8@0+ (1,0) [0|236] ""  BIU

BO_ 2564481453 EAM18DAE1AD: 8 EAM_HUD
 SG_ EAM18DAE1AD_DIAG_DATA : 7|64@0+ (1,0) [0|1.844674407371E+19] ""  C_ECU

BO_ 2564468193 CECU18DAADE1: 8 C_ECU
 SG_ CECU18DAADE1_DIAG_DATA : 7|64@0+ (1,0) [0|1.844674407371E+19] ""  EAM_HUD

BO_ 2564481359 PSM18DAE14F: 8 PSC
 SG_ PSM18DAE14F_DIAG_DATA : 7|64@0+ (1,0) [0|1.844674407371E+19] ""  C_ECU

BO_ 2564444129 CECU18DA4FE1: 8 C_ECU
 SG_ CECU18DA4FE1_DIAG_DATA : 7|64@0+ (1,0) [0|1.844674407371E+19] ""  PSC

BO_ 2564481406 PRG18DAE17E: 8 PRG
 SG_ PRG18DAE17E_DIAG_DATA : 7|64@0+ (1,0) [0|1.844674407371E+19] ""  C_ECU

BO_ 2564456161 CECU18DA7EE1: 8 C_ECU
 SG_ CECU18DA7EE1_DIAG_DATA : 7|64@0+ (1,0) [0|1.844674407371E+19] ""  PRG

BO_ 2564481346 AHL18DAE142: 8 AHL
 SG_ AHL18DAE142_DIAG_DATA : 7|64@0+ (1,0) [0|1.844674407371E+19] ""  C_ECU

BO_ 2564440801 CECU18DA42E1: 8 C_ECU
 SG_ CECU18DA42E1_DIAG_DATA : 7|64@0+ (1,0) [0|1.844674407371E+19] ""  AHL

BO_ 2564481398 TPM18DAE176: 8 TPM
 SG_ TPM18DAE176_DIAG_DATA : 7|64@0+ (1,0) [0|1.844674407371E+19] ""  C_ECU

BO_ 2564454113 CECU18DA76E1: 8 C_ECU
 SG_ CECU18DA76E1_DIAG_DATA : 7|64@0+ (1,0) [0|1.844674407371E+19] ""  TPM

BO_ 2564481313 BIU18DAE121: 8 BIU
 SG_ BIU18DAE121_DIAG_DATA : 7|64@0+ (1,0) [0|1.844674407371E+19] ""  C_ECU

BO_ 2564432353 CECU18DA21E1: 8 C_ECU
 SG_ CECU18DA21E1_DIAG_DATA : 7|64@0+ (1,0) [0|1.844674407371E+19] ""  BIU

BO_ 1774 CECU6EE: 8 C_ECU
 SG_ CECU6EE_7_0_DESTINATION_INFO : 57|2@0+ (1,0) [0|3] "" Vector__XXX
 SG_ CECU6EE_7_4_VEHICLE_SERIES : 62|3@0+ (1,0) [0|7] ""  ACN
 SG_ CECU6EE_6_0_DESTINATION_CODE : 53|6@0+ (1,0) [0|37] ""  DKY,BIU
 SG_ CECU6EE_5_0_EYE_VERSION_INFO : 41|2@0+ (1,0) [0|3] "" Vector__XXX
 SG_ CECU6EE_5_4_VEHICLE_TYPE : 44|1@0+ (1,0) [0|1] "" Vector__XXX
 SG_ CECU6EE_5_6_PRODUCTION_BASE : 46|1@0+ (1,0) [0|1] "" Vector__XXX
 SG_ CECU6EE_4_2_WHEEL_DRIVE_TYPE : 34|1@0+ (1,0) [0|1] "" Vector__XXX
 SG_ CECU6EE_4_3_3RD_SHEAT_EQUIPMENT : 35|1@0+ (1,0) [0|1] "" Vector__XXX
 SG_ CECU6EE_4_4_FLG_XMODE : 37|2@0+ (1,0) [0|3] "" Vector__XXX
 SG_ CECU6EE_4_6_ISS_EQUIPMENT : 38|1@0+ (1,0) [0|1] ""  SMT
 SG_ CECU6EE_4_7_TIRE_INFO : 31|9@0+ (1,0) [0|381] "" Vector__XXX
 SG_ CECU6EE_2_3_TIRE_TYPE : 23|5@0+ (1,0) [0|511] "" Vector__XXX
 SG_ CECU6EE_1_0_MSG_COUNTER : 11|4@0+ (1,0) [0|15] ""  ACN
 SG_ CECU6EE_1_5_BEV_WHEEL_DRIVE_TYPE : 14|2@0+ (1,0) [0|3] "" Vector__XXX
 SG_ CECU6EE_0_0_CHECK_SUM : 7|8@0+ (1,0) [0|255] ""  ACN

BO_ 1773 CECU6ED: 8 C_ECU
 SG_ CECU6ED_7_0_VEHICLE_TYPE_DETAIL : 59|4@0+ (1,0) [0|15] ""  ACN,BIU
 SG_ CECU6ED_7_7_STEERHEAT_EQUIPMENT : 63|1@0+ (1,0) [0|1] ""  ACN
 SG_ CECU6ED_6_0_SRH_EQUIPMENT : 48|1@0+ (1,0) [0|1] "" Vector__XXX
 SG_ CECU6ED_6_1_EMBENAVI_EQUIPMENT : 49|1@0+ (1,0) [0|1] "" Vector__XXX
 SG_ CECU6ED_6_2_RAB_EQUIPMENT_INFO : 50|1@0+ (1,0) [0|1] "" Vector__XXX
 SG_ CECU6ED_6_3_RRHEACON_EQUIPMENT : 51|1@0+ (1,0) [0|1] "" Vector__XXX
 SG_ CECU6ED_6_4_AUTOMIRROR_EQUIPMENT : 52|1@0+ (1,0) [0|1] "" Vector__XXX
 SG_ CECU6ED_6_5_SXMANTENNA_EQUIPMENT : 53|1@0+ (1,0) [0|1] "" Vector__XXX
 SG_ CECU6ED_6_7_SPORTSCONT_EQUIPMENT : 55|1@0+ (1,0) [0|1] "" Vector__XXX
 SG_ CECU6ED_5_0_TRANSMISSION_TYPE : 40|1@0+ (1,0) [0|1] ""  PRG,AHL,SMT
 SG_ CECU6ED_5_2_KICKSENSOR_EQUIPMENT : 42|1@0+ (1,0) [0|1] "" Vector__XXX
 SG_ CECU6ED_5_3_RRSEAT_OCCUPANT : 43|1@0+ (1,0) [0|1] "" Vector__XXX
 SG_ CECU6ED_5_4_HANDLE : 44|1@0+ (1,0) [0|1] ""  DKY,BIU
 SG_ CECU6ED_5_5_RRWIPER_EQUIPMENT : 45|1@0+ (1,0) [0|1] "" Vector__XXX
 SG_ CECU6ED_5_7_SRM_EQUIPMENT : 47|1@0+ (1,0) [0|1] "" Vector__XXX
 SG_ CECU6ED_4_0_VEHICLE_HEIGHT : 34|3@0+ (1,0) [0|7] "" Vector__XXX
 SG_ CECU6ED_4_4_SEATHEATER_EQUIPMENT : 37|2@0+ (1,0) [0|3] ""  ACN
 SG_ CECU6ED_3_0_YEAR_CHANGE : 27|4@0+ (1,0) [0|15] "" Vector__XXX
 SG_ CECU6ED_3_4_HEV_INFO : 30|3@0+ (1,0) [0|7] "" Vector__XXX
 SG_ CECU6ED_2_0_RRDIFF_TEMPLAMP_INFO : 17|2@0+ (1,0) [0|3] "" Vector__XXX
 SG_ CECU6ED_2_2_AHL_EQUIPMENT : 19|2@0+ (1,0) [0|3] "" Vector__XXX
 SG_ CECU6ED_2_4_LSD_TYPE : 23|4@0+ (1,0) [0|15] "" Vector__XXX
 SG_ CECU6ED_1_0_MSG_COUNTER : 11|4@0+ (1,0) [0|15] ""  PRG,SMT,ACN
 SG_ CECU6ED_1_5_WARNINGBOX_EQUIPMENT : 13|1@0+ (1,0) [0|1] "" Vector__XXX
 SG_ CECU6ED_0_0_CHECK_SUM : 7|8@0+ (1,0) [0|255] ""  PRG,SMT,ACN

BO_ 1772 CECU6EC: 8 C_ECU
 SG_ CECU6EC_7_0_ACC_B_EQUIPMENT : 63|8@0+ (1,0) [0|255] "" Vector__XXX
 SG_ CECU6EC_6_0_SMT_EQUIPMENT : 48|1@0+ (1,0) [0|1] ""  TPM
 SG_ CECU6EC_6_1_DCCD_EQUIPMENT : 49|1@0+ (1,0) [0|1] "" Vector__XXX
 SG_ CECU6EC_6_2_PRG_EQUIPMENT : 50|1@0+ (1,0) [0|1] ""  DKY,SMT,BIU
 SG_ CECU6EC_6_3_DKY_EQUIPMENT : 51|1@0+ (1,0) [0|1] ""  SMT
 SG_ CECU6EC_6_4_PSC_EQUIPMENT : 52|1@0+ (1,0) [0|1] ""  MCR,MCL
 SG_ CECU6EC_6_5_ILLUM_EQUIPMENT : 53|1@0+ (1,0) [0|1] "" Vector__XXX
 SG_ CECU6EC_6_6_CAB_EQUIPMENT : 54|1@0+ (1,0) [0|1] "" Vector__XXX
 SG_ CECU6EC_6_7_ACC_A_EQUIPMENT : 55|1@0+ (1,0) [0|1] "" Vector__XXX
 SG_ CECU6EC_5_0_CCU_EQUIPMENT : 40|1@0+ (1,0) [0|1] "" Vector__XXX
 SG_ CECU6EC_5_1_EAM_EQUIPMENT : 41|1@0+ (1,0) [0|1] "" Vector__XXX
 SG_ CECU6EC_5_2_RCR_L_EQUIPMENT : 42|1@0+ (1,0) [0|1] "" Vector__XXX
 SG_ CECU6EC_5_3_RCR_R_EQUIPMENT : 43|1@0+ (1,0) [0|1] "" Vector__XXX
 SG_ CECU6EC_5_4_FCR_L_EQUIPMENT : 44|1@0+ (1,0) [0|1] "" Vector__XXX
 SG_ CECU6EC_5_5_FCR_R_EQUIPMENT : 45|1@0+ (1,0) [0|1] "" Vector__XXX
 SG_ CECU6EC_5_6_VSS_EQUIPMENT : 46|1@0+ (1,0) [0|1] ""  ACN
 SG_ CECU6EC_5_7_RES_EQUIPMENT : 47|1@0+ (1,0) [0|1] "" Vector__XXX
 SG_ CECU6EC_4_0_LCT_EQUIPMENT : 32|1@0+ (1,0) [0|1] "" Vector__XXX
 SG_ CECU6EC_4_1_DAM_EQUIPMENT : 33|1@0+ (1,0) [0|1] "" Vector__XXX
 SG_ CECU6EC_4_2_MVS_EQUIPMENT : 34|1@0+ (1,0) [0|1] "" Vector__XXX
 SG_ CECU6EC_4_3_TCU_EQUIPMENT : 35|1@0+ (1,0) [0|1] "" Vector__XXX
 SG_ CECU6EC_4_4_TPM_EQUIPMENT : 36|1@0+ (1,0) [0|1] "" Vector__XXX
 SG_ CECU6EC_4_5_DCM_EQUIPMENT : 37|1@0+ (1,0) [0|1] "" Vector__XXX
 SG_ CECU6EC_4_6_MED_EQUIPMENT : 38|1@0+ (1,0) [0|1] "" Vector__XXX
 SG_ CECU6EC_4_7_MEP_EQUIPMENT : 39|1@0+ (1,0) [0|1] "" Vector__XXX
 SG_ CECU6EC_3_0_DATA_STATE : 24|1@0+ (1,0) [0|1] ""  ACN,BIU
 SG_ CECU6EC_3_1_EYE_EQUIPMENT : 25|1@0+ (1,0) [0|1] "" Vector__XXX
 SG_ CECU6EC_3_2_HEV_EQUIPMENT : 26|1@0+ (1,0) [0|1] "" Vector__XXX
 SG_ CECU6EC_3_3_SNR_EQUIPMENT : 27|1@0+ (1,0) [0|1] "" Vector__XXX
 SG_ CECU6EC_3_4_EPB_EQUIPMENT : 28|1@0+ (1,0) [0|1] "" Vector__XXX
 SG_ CECU6EC_3_5_DMS_EQUIPMENT : 29|1@0+ (1,0) [0|1] ""  ACN
 SG_ CECU6EC_3_6_BST_EQUIPMENT : 30|1@0+ (1,0) [0|1] "" Vector__XXX
 SG_ CECU6EC_3_7_MCA_EQUIPMENT : 31|1@0+ (1,0) [0|1] "" Vector__XXX
 SG_ CECU6EC_1_0_MSG_COUNTER : 11|4@0+ (1,0) [0|15] ""  SMT,ACN
 SG_ CECU6EC_0_0_CHECK_SUM : 7|8@0+ (1,0) [0|255] ""  SMT,ACN

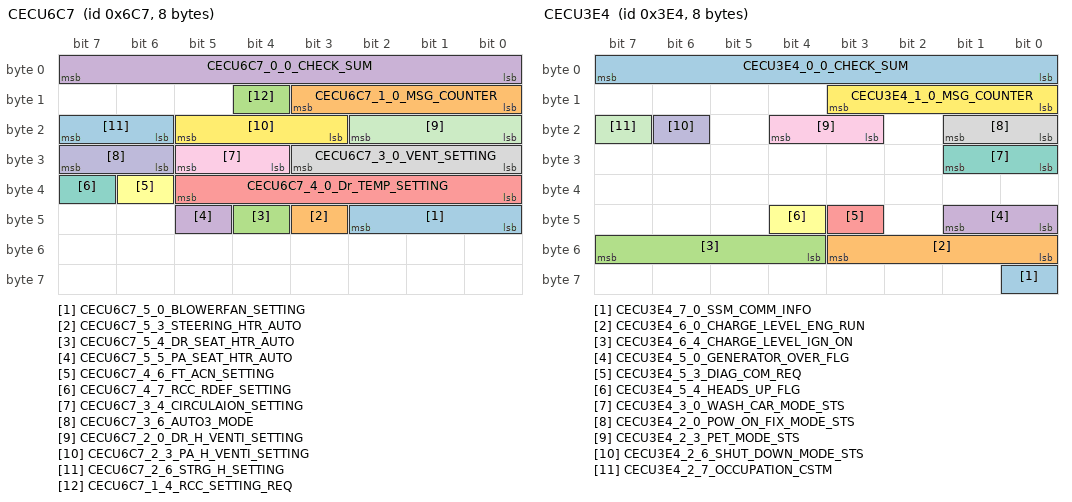
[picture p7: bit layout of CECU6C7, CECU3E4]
BO_ 1735 CECU6C7: 8 C_ECU
 SG_ CECU6C7_5_0_BLOWERFAN_SETTING : 42|3@0+ (1,0) [0|7] ""  ACN
 SG_ CECU6C7_5_3_STEERING_HTR_AUTO : 43|1@0+ (1,0) [0|1] ""  ACN
 SG_ CECU6C7_5_4_DR_SEAT_HTR_AUTO : 44|1@0+ (1,0) [0|1] ""  ACN
 SG_ CECU6C7_5_5_PA_SEAT_HTR_AUTO : 45|1@0+ (1,0) [0|1] ""  ACN
 SG_ CECU6C7_4_0_Dr_TEMP_SETTING : 37|6@0+ (1,0) [0|63] ""  ACN
 SG_ CECU6C7_4_6_FT_ACN_SETTING : 38|1@0+ (1,0) [0|1] ""  ACN
 SG_ CECU6C7_4_7_RCC_RDEF_SETTING : 39|1@0+ (1,0) [0|1] ""  ACN
 SG_ CECU6C7_3_0_VENT_SETTING : 27|4@0+ (1,0) [0|21] ""  ACN
 SG_ CECU6C7_3_4_CIRCULAION_SETTING : 29|2@0+ (1,0) [0|3] ""  ACN
 SG_ CECU6C7_3_6_AUTO3_MODE : 31|2@0+ (1,0) [0|3] ""  ACN
 SG_ CECU6C7_2_0_DR_H_VENTI_SETTING : 18|3@0+ (1,0) [0|7] ""  ACN
 SG_ CECU6C7_2_3_PA_H_VENTI_SETTING : 21|3@0+ (1,0) [0|7] ""  ACN
 SG_ CECU6C7_2_6_STRG_H_SETTING : 23|2@0+ (1,0) [0|2] ""  ACN
 SG_ CECU6C7_1_0_MSG_COUNTER : 11|4@0+ (1,0) [0|15] ""  ACN
 SG_ CECU6C7_1_4_RCC_SETTING_REQ : 12|1@0+ (1,0) [0|1] ""  ACN
 SG_ CECU6C7_0_0_CHECK_SUM : 7|8@0+ (1,0) [0|255] ""  ACN

BO_ 996 CECU3E4: 8 C_ECU
 SG_ CECU3E4_7_0_SSM_COMM_INFO : 56|1@0+ (1,0) [0|1] "" Vector__XXX
 SG_ CECU3E4_6_0_CHARGE_LEVEL_ENG_RUN : 51|4@0+ (1,0) [0|9] "" Vector__XXX
 SG_ CECU3E4_6_4_CHARGE_LEVEL_IGN_ON : 55|4@0+ (1,0) [0|9] ""  ACN
 SG_ CECU3E4_5_0_GENERATOR_OVER_FLG : 41|2@0+ (1,0) [0|3] "" Vector__XXX
 SG_ CECU3E4_5_3_DIAG_COM_REQ : 43|1@0+ (1,0) [0|1] "" Vector__XXX
 SG_ CECU3E4_5_4_HEADS_UP_FLG : 44|1@0+ (1,0) [0|1] "" Vector__XXX
 SG_ CECU3E4_3_0_WASH_CAR_MODE_STS : 25|2@0+ (1,0) [0|3] ""  SMT
 SG_ CECU3E4_2_0_POW_ON_FIX_MODE_STS : 17|2@0+ (1,0) [0|3] ""  SMT
 SG_ CECU3E4_2_3_PET_MODE_STS : 20|2@0+ (1,0) [0|3] ""  BIU
 SG_ CECU3E4_2_6_SHUT_DOWN_MODE_STS : 22|1@0+ (1,0) [0|1] "" Vector__XXX
 SG_ CECU3E4_2_7_OCCUPATION_CSTM : 23|1@0+ (1,0) [0|1] "" Vector__XXX
 SG_ CECU3E4_1_0_MSG_COUNTER : 11|4@0+ (1,0) [0|15] ""  SMT,ACN
 SG_ CECU3E4_0_0_CHECK_SUM : 7|8@0+ (1,0) [0|255] ""  SMT,ACN

BO_ 1280 CGW500: 8 C_ECU
 SG_ CGW500_1_4_ActiveWakeUpBit : 12|1@1+ (1,0) [0|1] ""  PSC,MCR,MCL,PRG,SMT,TPM,BIU
 SG_ CGW500_0_0_SourceNodeID : 0|8@1+ (1,0) [0|255] ""  PSC,MCR,MCL,PRG,SMT,TPM,BIU

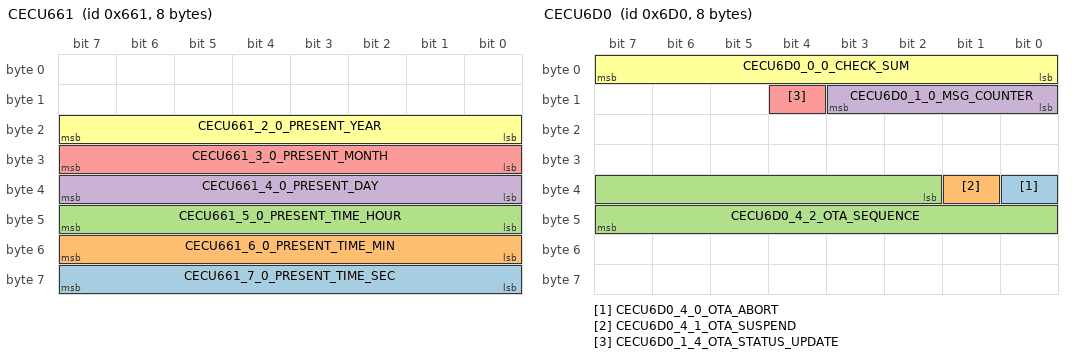
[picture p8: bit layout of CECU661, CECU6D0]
BO_ 1633 CECU661: 8 C_ECU
 SG_ CECU661_7_0_PRESENT_TIME_SEC : 63|8@0+ (1,0) [0|89] "s"  DKY,PSC,MCR,MCL,PRG,ACN
 SG_ CECU661_6_0_PRESENT_TIME_MIN : 55|8@0+ (1,0) [0|89] "m"  DKY,PSC,MCR,MCL,PRG,ACN
 SG_ CECU661_5_0_PRESENT_TIME_HOUR : 47|8@0+ (1,0) [0|35] "h"  DKY,PSC,MCR,MCL,PRG,ACN
 SG_ CECU661_4_0_PRESENT_DAY : 39|8@0+ (1,0) [1|49] "Day"  DKY,PSC,MCR,MCL,PRG,ACN
 SG_ CECU661_3_0_PRESENT_MONTH : 31|8@0+ (1,0) [1|18] "Month"  DKY,PSC,MCR,MCL,PRG,ACN
 SG_ CECU661_2_0_PRESENT_YEAR : 23|8@0+ (1,0) [0|153] "Year"  DKY,PSC,MCR,MCL,PRG,ACN

BO_ 1632 CGW660: 8 C_ECU
 SG_ CGW660_7_0_COUNT_TIME : 47|24@0+ (100,0) [0|1677721400] "ms"  DKY,PSC,MCR,MCL,PRG,AHL,SMT,ACN,EAM_HUD,DAM,BIU
 SG_ CGW660_3_0_COUNT_TRIP : 23|16@0+ (1,0) [0|65534] "trip"  PSC,MCR,MCL,PRG,AHL,SMT,ACN,EAM_HUD,DAM,BIU
 SG_ CGW660_1_0_SUB_ID : 7|16@0+ (1,0) [0|65535] "" Vector__XXX

BO_ 1744 CECU6D0: 8 C_ECU
 SG_ CECU6D0_4_0_OTA_ABORT : 32|1@1+ (1,0) [0|1] "" Vector__XXX
 SG_ CECU6D0_4_1_OTA_SUSPEND : 33|1@1+ (1,0) [0|1] "" Vector__XXX
 SG_ CECU6D0_4_2_OTA_SEQUENCE : 34|14@1+ (1,0) [0|33170] "" Vector__XXX
 SG_ CECU6D0_1_0_MSG_COUNTER : 8|4@1+ (1,0) [0|15] "" Vector__XXX
 SG_ CECU6D0_1_4_OTA_STATUS_UPDATE : 12|1@1+ (1,0) [0|0] ""  BIU
 SG_ CECU6D0_0_0_CHECK_SUM : 0|8@1+ (1,0) [0|255] "" Vector__XXX

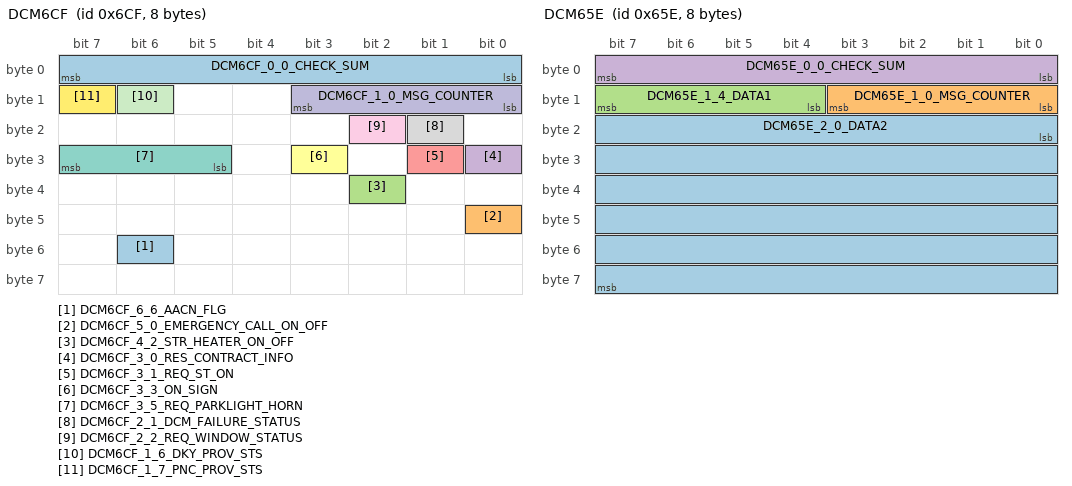
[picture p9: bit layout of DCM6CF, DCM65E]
BO_ 1743 DCM6CF: 8 C_ECU_GW
 SG_ DCM6CF_6_6_AACN_FLG : 54|1@1+ (1,0) [0|1] "" Vector__XXX
 SG_ DCM6CF_5_0_EMERGENCY_CALL_ON_OFF : 40|1@1+ (1,0) [0|1] "" Vector__XXX
 SG_ DCM6CF_4_2_STR_HEATER_ON_OFF : 34|1@1+ (1,0) [0|1] "" Vector__XXX
 SG_ DCM6CF_3_0_RES_CONTRACT_INFO : 24|1@1+ (1,0) [0|1] "" Vector__XXX
 SG_ DCM6CF_3_1_REQ_ST_ON : 25|1@1+ (1,0) [0|1] ""  BIU
 SG_ DCM6CF_3_3_ON_SIGN : 27|1@1+ (1,0) [0|1] ""  BIU
 SG_ DCM6CF_3_5_REQ_PARKLIGHT_HORN : 29|3@1+ (1,0) [0|7] ""  BIU
 SG_ DCM6CF_2_1_DCM_FAILURE_STATUS : 17|1@1+ (1,0) [0|1] "" Vector__XXX
 SG_ DCM6CF_2_2_REQ_WINDOW_STATUS : 18|1@1+ (1,0) [0|1] ""  BIU
 SG_ DCM6CF_1_0_MSG_COUNTER : 8|4@1+ (1,0) [0|15] ""  BIU
 SG_ DCM6CF_1_6_DKY_PROV_STS : 14|1@1+ (1,0) [0|1] ""  DKY
 SG_ DCM6CF_1_7_PNC_PROV_STS : 15|1@1+ (1,0) [0|1] "" Vector__XXX
 SG_ DCM6CF_0_0_CHECK_SUM : 0|8@1+ (1,0) [0|255] ""  BIU

BO_ 1630 DCM65E: 8 C_ECU_GW
 SG_ DCM65E_2_0_DATA2 : 16|48@1+ (1,0) [0|281474976710660] ""  SMT,BIU
 SG_ DCM65E_1_0_MSG_COUNTER : 8|4@1+ (1,0) [0|15] ""  BIU
 SG_ DCM65E_1_4_DATA1 : 12|4@1+ (1,0) [0|15] ""  SMT,BIU
 SG_ DCM65E_0_0_CHECK_SUM : 0|8@1+ (1,0) [0|255] ""  BIU

BO_ 1749 CECU6D5: 8 C_ECU
 SG_ CECU6D5_6_0_CSTM_FMHD : 48|3@1+ (1,0) [0|7] "" Vector__XXX
 SG_ CECU6D5_5_0_CSTM_WRH : 40|1@1+ (1,0) [0|1] "" Vector__XXX
 SG_ CECU6D5_5_1_CSTM_LMHD : 41|2@1+ (1,0) [0|3] "" Vector__XXX
 SG_ CECU6D5_5_3 : 43|2@1+ (1,0) [0|3] "" Vector__XXX
 SG_ CECU6D5_5_5_CSTM_HBA : 45|2@1+ (1,0) [0|3] "" Vector__XXX
 SG_ CECU6D5_5_7_ADB_ACTIVE : 47|1@1+ (1,0) [0|1] "" Vector__XXX
 SG_ CECU6D5_4_0_JUDGE_ILL : 32|1@1+ (1,0) [0|1] ""  AHL
 SG_ CECU6D5_4_1_HEADLAMP_AUTO_SW : 33|1@1+ (1,0) [0|1] ""  AHL
 SG_ CECU6D5_4_2_IND_ACTIVE_HBA : 34|2@1+ (1,0) [0|3] ""  BIU
 SG_ CECU6D5_4_4_FGT_LGTOFF_WARNING : 36|1@1+ (1,0) [0|1] ""  BIU
 SG_ CECU6D5_3_0_CRN_R_REQ : 24|2@1+ (1,0) [0|3] ""  BIU
 SG_ CECU6D5_3_2_CRN_L_REQ : 26|2@1+ (1,0) [0|3] ""  BIU
 SG_ CECU6D5_3_4_FMH : 28|1@1+ (1,0) [0|1] ""  BIU
 SG_ CECU6D5_3_5_LMH : 29|1@1+ (1,0) [0|1] ""  BIU
 SG_ CECU6D5_2_0_LGT_1 : 16|1@1+ (1,0) [0|1] ""  BIU
 SG_ CECU6D5_2_1_LGT_LO : 17|1@1+ (1,0) [0|1] ""  BIU
 SG_ CECU6D5_2_2_LGT_HI : 18|2@1+ (1,0) [0|1] ""  BIU
 SG_ CECU6D5_2_4_FFOG_RELAY_REQ : 20|1@1+ (1,0) [0|1] ""  BIU
 SG_ CECU6D5_2_5_RFOG_RELAY_REQ : 21|1@1+ (1,0) [0|1] ""  BIU
 SG_ CECU6D5_2_6_LGT_DRL : 22|1@1+ (1,0) [0|1] ""  BIU
 SG_ CECU6D5_1_0_MSG_COUNTER : 8|4@1+ (1,0) [0|15] ""  ACN,BIU
 SG_ CECU6D5_0_0_CHECK_SUM : 0|8@1+ (1,0) [0|255] ""  ACN,BIU

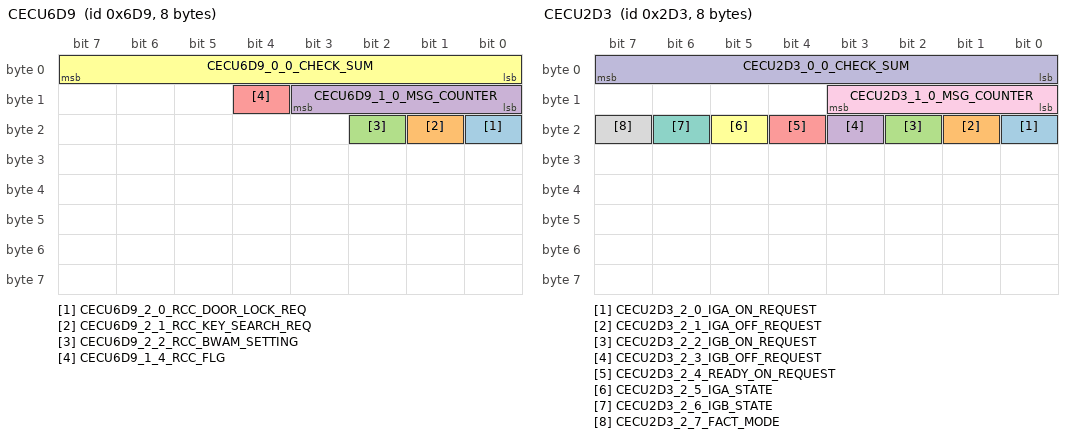
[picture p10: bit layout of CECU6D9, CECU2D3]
BO_ 1753 CECU6D9: 8 C_ECU
 SG_ CECU6D9_2_0_RCC_DOOR_LOCK_REQ : 16|1@1+ (1,0) [0|1] ""  BIU
 SG_ CECU6D9_2_1_RCC_KEY_SEARCH_REQ : 17|1@1+ (1,0) [0|1] ""  SMT
 SG_ CECU6D9_2_2_RCC_BWAM_SETTING : 18|1@1+ (1,0) [0|1] "" Vector__XXX
 SG_ CECU6D9_1_0_MSG_COUNTER : 8|4@1+ (1,0) [0|15] ""  SMT,ACN,BIU
 SG_ CECU6D9_1_4_RCC_FLG : 12|1@1+ (1,0) [0|1] ""  DKY,SMT,ACN,BIU
 SG_ CECU6D9_0_0_CHECK_SUM : 0|8@1+ (1,0) [0|255] ""  SMT,ACN,BIU

BO_ 723 CECU2D3: 8 C_ECU
 SG_ CECU2D3_2_0_IGA_ON_REQUEST : 16|1@1+ (1,0) [0|1] ""  SMT
 SG_ CECU2D3_2_1_IGA_OFF_REQUEST : 17|1@1+ (1,0) [0|1] ""  SMT
 SG_ CECU2D3_2_2_IGB_ON_REQUEST : 18|1@1+ (1,0) [0|1] ""  SMT
 SG_ CECU2D3_2_3_IGB_OFF_REQUEST : 19|1@1+ (1,0) [0|1] ""  SMT
 SG_ CECU2D3_2_4_READY_ON_REQUEST : 20|1@1+ (1,0) [0|1] ""  SMT
 SG_ CECU2D3_2_5_IGA_STATE : 21|1@1+ (1,0) [0|1] ""  DKY,SMT,ACN
 SG_ CECU2D3_2_6_IGB_STATE : 22|1@1+ (1,0) [0|1] ""  DKY,SMT,ACN
 SG_ CECU2D3_2_7_FACT_MODE : 23|1@1+ (1,0) [0|1] ""  SMT
 SG_ CECU2D3_1_0_MSG_COUNTER : 8|4@1+ (1,0) [0|15] ""  SMT,ACN
 SG_ CECU2D3_0_0_CHECK_SUM : 0|8@1+ (1,0) [0|255] ""  SMT,ACN

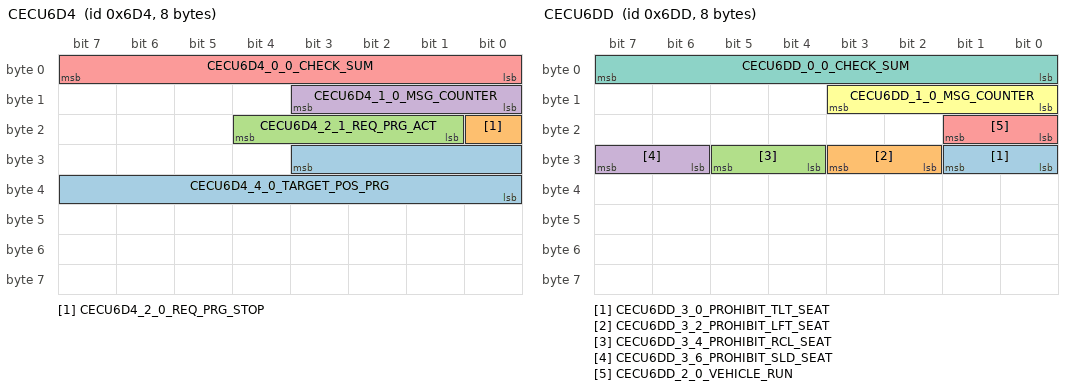
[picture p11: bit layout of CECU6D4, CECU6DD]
BO_ 1748 CECU6D4: 8 C_ECU
 SG_ CECU6D4_4_0_TARGET_POS_PRG : 27|12@0+ (1,0) [0|4095] ""  PRG
 SG_ CECU6D4_2_0_REQ_PRG_STOP : 16|1@0+ (1,0) [0|1] ""  PRG
 SG_ CECU6D4_2_1_REQ_PRG_ACT : 20|4@0+ (1,0) [0|5] ""  PRG
 SG_ CECU6D4_1_0_MSG_COUNTER : 11|4@0+ (1,0) [0|15] ""  PRG
 SG_ CECU6D4_0_0_CHECK_SUM : 7|8@0+ (1,0) [0|255] ""  PRG

BO_ 1757 CECU6DD: 8 C_ECU
 SG_ CECU6DD_3_0_PROHIBIT_TLT_SEAT : 25|2@0+ (1,0) [0|3] ""  PSC
 SG_ CECU6DD_3_2_PROHIBIT_LFT_SEAT : 27|2@0+ (1,0) [0|3] ""  PSC
 SG_ CECU6DD_3_4_PROHIBIT_RCL_SEAT : 29|2@0+ (1,0) [0|3] ""  PSC
 SG_ CECU6DD_3_6_PROHIBIT_SLD_SEAT : 31|2@0+ (1,0) [0|3] ""  PSC
 SG_ CECU6DD_2_0_VEHICLE_RUN : 17|2@0+ (1,0) [0|3] ""  PSC
 SG_ CECU6DD_1_0_MSG_COUNTER : 11|4@0+ (1,0) [0|15] ""  PSC
 SG_ CECU6DD_0_0_CHECK_SUM : 7|8@0+ (1,0) [0|255] ""  PSC

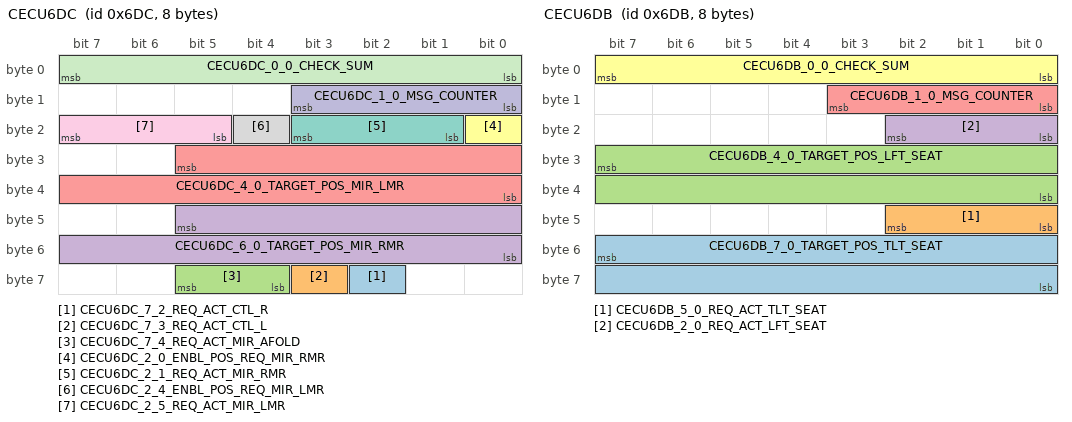
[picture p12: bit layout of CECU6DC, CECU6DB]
BO_ 1756 CECU6DC: 8 C_ECU
 SG_ CECU6DC_7_2_REQ_ACT_CTL_R : 58|1@0+ (1,0) [0|1] ""  MCR
 SG_ CECU6DC_7_3_REQ_ACT_CTL_L : 59|1@0+ (1,0) [0|1] ""  MCL
 SG_ CECU6DC_7_4_REQ_ACT_MIR_AFOLD : 61|2@0+ (1,0) [0|3] ""  MCR,MCL
 SG_ CECU6DC_6_0_TARGET_POS_MIR_RMR : 45|14@0+ (1,0) [0|16383] "mV"  MCR
 SG_ CECU6DC_4_0_TARGET_POS_MIR_LMR : 29|14@0+ (1,0) [0|16383] "mV"  MCL
 SG_ CECU6DC_2_0_ENBL_POS_REQ_MIR_RMR : 16|1@0+ (1,0) [0|1] ""  MCR
 SG_ CECU6DC_2_1_REQ_ACT_MIR_RMR : 19|3@0+ (1,0) [0|7] ""  MCR
 SG_ CECU6DC_2_4_ENBL_POS_REQ_MIR_LMR : 20|1@0+ (1,0) [0|1] ""  MCL
 SG_ CECU6DC_2_5_REQ_ACT_MIR_LMR : 23|3@0+ (1,0) [0|7] ""  MCL
 SG_ CECU6DC_1_0_MSG_COUNTER : 11|4@0+ (1,0) [0|15] ""  MCR,MCL
 SG_ CECU6DC_0_0_CHECK_SUM : 7|8@0+ (1,0) [0|255] ""  MCR,MCL

BO_ 1755 CECU6DB: 8 C_ECU
 SG_ CECU6DB_7_0_TARGET_POS_TLT_SEAT : 55|16@0+ (1,0) [0|65535] "count"  PSC
 SG_ CECU6DB_5_0_REQ_ACT_TLT_SEAT : 42|3@0+ (1,0) [0|7] ""  PSC
 SG_ CECU6DB_4_0_TARGET_POS_LFT_SEAT : 31|16@0+ (1,0) [0|65535] "count"  PSC
 SG_ CECU6DB_2_0_REQ_ACT_LFT_SEAT : 18|3@0+ (1,0) [0|7] ""  PSC
 SG_ CECU6DB_1_0_MSG_COUNTER : 11|4@0+ (1,0) [0|15] ""  PSC
 SG_ CECU6DB_0_0_CHECK_SUM : 7|8@0+ (1,0) [0|255] ""  PSC

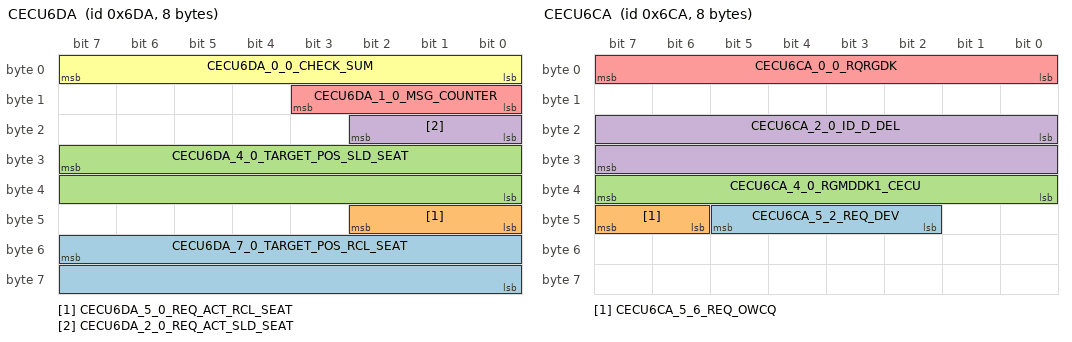
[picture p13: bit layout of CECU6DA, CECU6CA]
BO_ 1754 CECU6DA: 8 C_ECU
 SG_ CECU6DA_7_0_TARGET_POS_RCL_SEAT : 55|16@0+ (1,0) [0|65535] "count"  PSC
 SG_ CECU6DA_5_0_REQ_ACT_RCL_SEAT : 42|3@0+ (1,0) [0|7] ""  PSC
 SG_ CECU6DA_4_0_TARGET_POS_SLD_SEAT : 31|16@0+ (1,0) [0|65535] "count"  PSC
 SG_ CECU6DA_2_0_REQ_ACT_SLD_SEAT : 18|3@0+ (1,0) [0|7] ""  PSC
 SG_ CECU6DA_1_0_MSG_COUNTER : 11|4@0+ (1,0) [0|15] ""  PSC
 SG_ CECU6DA_0_0_CHECK_SUM : 7|8@0+ (1,0) [0|255] ""  PSC

BO_ 1738 CECU6CA: 8 C_ECU
 SG_ CECU6CA_5_2_REQ_DEV : 42|4@1+ (1,0) [0|15] ""  SMT
 SG_ CECU6CA_5_6_REQ_OWCQ : 46|2@1+ (1,0) [0|2] ""  SMT
 SG_ CECU6CA_4_0_RGMDDK1_CECU : 32|8@1+ (1,0) [0|40] ""  SMT
 SG_ CECU6CA_2_0_ID_D_DEL : 16|16@1+ (1,0) [0|65535] ""  DKY
 SG_ CECU6CA_0_0_RQRGDK : 0|8@1+ (1,0) [0|54] ""  DKY

BO_ 1576 CECU628: 8 C_ECU
 SG_ CECU628_3_4_CAN_MCC : 28|12@1+ (1,0) [0|999] ""  DKY
 SG_ CECU628_1_0_MSG_COUNTER : 8|4@1+ (1,0) [0|15] ""  DKY
 SG_ CECU628_0_0_CHECKSUM : 0|8@1+ (1,0) [0|255] ""  DKY

BO_ 1699 CECU6A3: 8 C_ECU
 SG_ CECU6A3_7_4_ACC4ONOFF : 60|1@1+ (1,0) [0|0] "" Vector__XXX
 SG_ CECU6A3_7_5_ACC3ONOFF : 61|1@1+ (1,0) [0|0] "" Vector__XXX
 SG_ CECU6A3_7_6_ACC2ONOFF : 62|1@1+ (1,0) [0|0] "" Vector__XXX
 SG_ CECU6A3_7_7_ACC1ONOFF : 63|1@1+ (1,0) [0|0] "" Vector__XXX
 SG_ CECU6A3_6_0_CAB_SYSC_EQUIPMENT : 48|1@1+ (1,0) [0|0] "" Vector__XXX
 SG_ CECU6A3_6_1_CAB_SYSB_EQUIPMENT : 49|1@1+ (1,0) [0|0] "" Vector__XXX
 SG_ CECU6A3_6_2_CAB_SYSA_EQUIPMENT : 50|1@1+ (1,0) [0|0] "" Vector__XXX
 SG_ CECU6A3_6_3_CAB_EQUIPMENT : 51|1@1+ (1,0) [0|0] "" Vector__XXX
 SG_ CECU6A3_6_4_ACC_B_ONOFF : 52|1@1+ (1,0) [0|0] "" Vector__XXX
 SG_ CECU6A3_6_5_ACC_B_EQUIPMENT : 53|1@1+ (1,0) [0|0] "" Vector__XXX
 SG_ CECU6A3_6_6_ACC_A_ONOFF : 54|1@1+ (1,0) [0|0] "" Vector__XXX
 SG_ CECU6A3_6_7_ACC_A_EQUIPMENT : 55|1@1+ (1,0) [0|0] "" Vector__XXX
 SG_ CECU6A3_5_0_AMBI_ILLUM_SPEC : 40|1@1+ (1,0) [0|0] "" Vector__XXX
 SG_ CECU6A3_4_6_SI_DRIVE_S : 38|1@1+ (1,0) [0|0] "" Vector__XXX
 SG_ CECU6A3_4_5_SI_DRIVE_I : 37|1@1+ (1,0) [0|0] "" Vector__XXX
 SG_ CECU6A3_4_4_SI_DRIVE_ECO : 36|1@1+ (1,0) [0|0] "" Vector__XXX
 SG_ CECU6A3_4_3_TOWING_OPT : 35|1@1+ (1,0) [0|0] "" Vector__XXX
 SG_ CECU6A3_3_4_MOTOR_GENERAT_OUTPUT : 28|1@1+ (1,0) [0|0] "" Vector__XXX
 SG_ CECU6A3_3_0_HIGH_VOLT_CAPACITY : 24|1@1+ (1,0) [0|0] "" Vector__XXX
 SG_ CECU6A3_2_4_REAR_WHEEL_STEER : 20|1@1+ (1,0) [0|0] "" Vector__XXX
 SG_ CECU6A3_2_0_POWER_CHARGE : 16|1@1+ (1,0) [0|0] "" Vector__XXX
 SG_ CECU6A3_1_5_ACOUTLET_EQUIPMENT : 13|1@1+ (1,0) [0|0] "" Vector__XXX
 SG_ CECU6A3_1_0_MSG_COUNTER : 8|1@1+ (1,0) [0|0] "" Vector__XXX
 SG_ CECU6A3_0_0_CHECK_SUM : 0|1@1+ (1,0) [0|0] "" Vector__XXX

BO_ 1739 DCM6CB: 8 C_ECU_GW
 SG_ DCM6CB_7_0 : 56|40@1+ (1,0) [0|1099511627775] "" Vector__XXX
 SG_ DCM6CB_5_0_DKY_SLOT_ID : 40|16@1+ (1,0) [0|65535] "" Vector__XXX
 SG_ DCM6CB_4_0_DKY_COM_REQ : 32|4@1+ (1,0) [0|18] "" Vector__XXX
 SG_ DCM6CB_3_5_PNC_SW_REQ_SRV : 29|3@1+ (1,0) [0|5] "" Vector__XXX
 SG_ DCM6CB_2_0_SHUTDOWN_REQ : 16|1@1+ (1,0) [0|1] "" Vector__XXX
 SG_ DCM6CB_2_3_IGB_OFF_REQUEST : 19|1@1+ (1,0) [0|1] "" Vector__XXX
 SG_ DCM6CB_2_4_IGB_ON_REQUEST : 20|1@1+ (1,0) [0|1] "" Vector__XXX
 SG_ DCM6CB_2_5_REARGATE_UNLOCK_REQ : 21|1@1+ (1,0) [0|1] ""  BIU
 SG_ DCM6CB_2_6_DOOR_UNLOCK_REQ : 22|1@1+ (1,0) [0|1] ""  BIU
 SG_ DCM6CB_2_7_DOOR_LOCK_REQUEST : 23|1@1+ (1,0) [0|1] ""  BIU
 SG_ DCM6CB_1_0_MSG_COUNTER : 8|4@1+ (1,0) [0|15] ""  BIU
 SG_ DCM6CB_1_4_REQ_SVR_HAZARD_ON : 12|1@1+ (1,0) [0|1] ""  BIU
 SG_ DCM6CB_1_5_HORNHZRD_DEACT_REQ : 13|1@1+ (1,0) [0|1] ""  BIU
 SG_ DCM6CB_1_6_HAZARD_ACT_REQ : 14|1@1+ (1,0) [0|1] ""  BIU
 SG_ DCM6CB_1_7_HORNHAZARD_ACT_REQ : 15|1@1+ (1,0) [0|1] ""  BIU
 SG_ DCM6CB_0_0_CHECK_SUM : 0|8@1+ (1,0) [0|255] ""  BIU

BO_ 1361 EAM551: 8 EAM_HUD
 SG_ EAM551_0_0_NETWORK_STATUS : 0|64@1+ (1,0) [0|0] ""  C_ECU

BO_ 1677 MET68D: 8 C_ECU_GW
 SG_ MET68D_7_0_STATUS_WASHER_LAMP : 56|1@1+ (1,0) [0|1] "" Vector__XXX
 SG_ MET68D_7_1_OILPRESSURE_SW : 57|1@1+ (1,0) [0|1] "" Vector__XXX
 SG_ MET68D_7_2_FLG_EAM : 58|1@1+ (1,0) [0|1] "" Vector__XXX
 SG_ MET68D_7_3_CSTM_IND_RED : 59|1@1+ (1,0) [0|1] ""  EAM_HUD
 SG_ MET68D_7_4_CSTM_IND_YELLOW : 60|1@1+ (1,0) [0|1] ""  EAM_HUD
 SG_ MET68D_7_5_CSTM_IND_GREEN : 61|1@1+ (1,0) [0|1] ""  EAM_HUD
 SG_ MET68D_7_6_REQ_CSTM_SRH : 62|1@1+ (1,0) [0|1] ""  AHL
 SG_ MET68D_7_7_CSTM_SRH : 63|1@1+ (1,0) [0|1] ""  AHL
 SG_ MET68D_6_5_REQ_CHG_CSTM_RAB : 53|1@1+ (1,0) [0|1] "" Vector__XXX
 SG_ MET68D_6_6_CSTM_RAB : 54|1@1+ (1,0) [0|1] "" Vector__XXX
 SG_ MET68D_6_7_CSTM_SONNER : 55|1@1+ (1,0) [0|1] "" Vector__XXX
 SG_ MET68D_5_0_TEMP_FOR_PPA : 40|13@1- (0.1,-400) [-400|419.1] "℃" Vector__XXX
 SG_ MET68D_2_0_ODO : 16|24@1+ (0.1,0) [0|999999.9] "km"  DKY,BIU
 SG_ MET68D_1_0_MSG_COUNTER : 8|4@1+ (1,0) [0|15] ""  BIU
 SG_ MET68D_1_4_RESET_CSTM_TPMS_RAEB : 12|1@1+ (1,0) [0|1] ""  AHL,TPM
 SG_ MET68D_1_5_REQ_CHG_CSTM_TPMS : 13|1@1+ (1,0) [0|1] ""  TPM
 SG_ MET68D_1_6_CSTM_TIRE_UNIT : 14|2@1+ (1,0) [0|3] ""  TPM
 SG_ MET68D_0_0_CHECK_SUM : 0|8@1+ (1,0) [0|255] ""  BIU

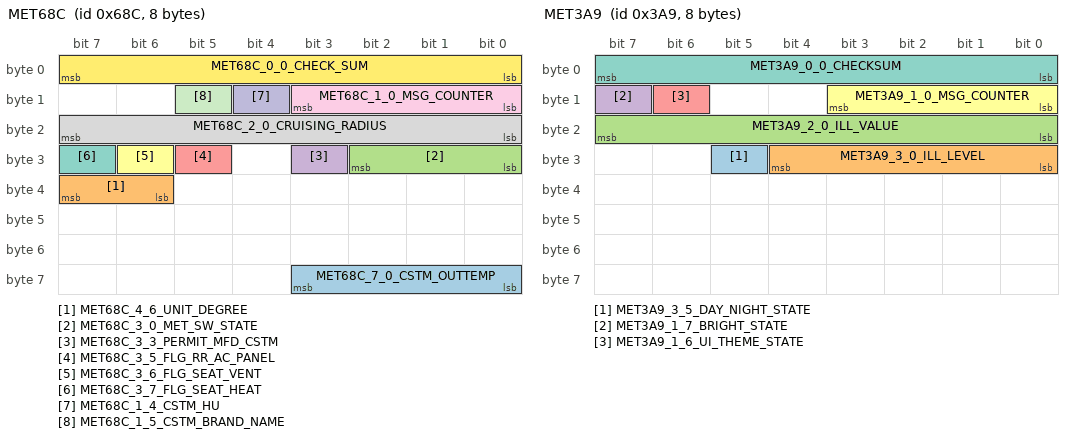
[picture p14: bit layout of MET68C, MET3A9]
BO_ 1676 MET68C: 8 C_ECU_GW
 SG_ MET68C_7_0_CSTM_OUTTEMP : 56|4@1+ (1,0) [0|15] "℃" Vector__XXX
 SG_ MET68C_4_6_UNIT_DEGREE : 38|2@1+ (1,0) [0|3] ""  ACN
 SG_ MET68C_3_0_MET_SW_STATE : 24|3@1+ (1,0) [0|3] "" Vector__XXX
 SG_ MET68C_3_3_PERMIT_MFD_CSTM : 27|1@1+ (1,0) [0|1] "" Vector__XXX
 SG_ MET68C_3_5_FLG_RR_AC_PANEL : 29|1@1+ (1,0) [0|1] "" Vector__XXX
 SG_ MET68C_3_6_FLG_SEAT_VENT : 30|1@1+ (1,0) [0|1] "" Vector__XXX
 SG_ MET68C_3_7_FLG_SEAT_HEAT : 31|1@1+ (1,0) [0|1] "" Vector__XXX
 SG_ MET68C_2_0_CRUISING_RADIUS : 16|8@1+ (10,0) [10|2540] "km(mile)" Vector__XXX
 SG_ MET68C_1_0_MSG_COUNTER : 8|4@1+ (1,0) [0|15] ""  ACN
 SG_ MET68C_1_4_CSTM_HU : 12|1@1+ (1,0) [0|1] "" Vector__XXX
 SG_ MET68C_1_5_CSTM_BRAND_NAME : 13|1@1+ (1,0) [0|1] "" Vector__XXX
 SG_ MET68C_0_0_CHECK_SUM : 0|8@1+ (1,0) [0|255] ""  ACN

BO_ 915 MET393: 8 C_ECU_GW
 SG_ MET393_7_0_REQ_CHG_CSTM_EYE : 56|1@1+ (1,0) [0|1] "" Vector__XXX
 SG_ MET393_7_1_REQ_RESET_CSTM_EYE : 57|1@1+ (1,0) [0|1] "" Vector__XXX
 SG_ MET393_7_2_CSTM_ALK : 58|1@1+ (1,0) [0|1] "" Vector__XXX
 SG_ MET393_7_3_CSTM_HBA : 59|1@1+ (1,0) [0|1] "" Vector__XXX
 SG_ MET393_7_4_CSTM_MIS_AT_BACK : 60|2@1+ (1,0) [0|3] "" Vector__XXX
 SG_ MET393_7_6_CSTM_ACC_CONT : 62|2@1+ (1,0) [0|3] "" Vector__XXX
 SG_ MET393_6_0_R_DIFF_TEMP : 48|8@1+ (1,-50) [-50|200] "℃" Vector__XXX
 SG_ MET393_5_2_WARN_R_DIFF_TEMP : 42|2@1+ (1,0) [0|3] "" Vector__XXX
 SG_ MET393_5_4_ADAPTIVECC_NOALIVE : 44|1@1+ (1,0) [0|1] "" Vector__XXX
 SG_ MET393_5_5_DUAL_RANGE_LO : 45|1@1+ (1,0) [0|1] "" Vector__XXX
 SG_ MET393_5_6_CSTM_SPD_LIMITER : 46|1@1+ (1,0) [0|1] "" Vector__XXX
 SG_ MET393_5_7_CSTM_LANE_CONT : 47|1@1+ (1,0) [0|1] "" Vector__XXX
 SG_ MET393_4_0_FUEL_LEVEL_RESIST : 32|10@1+ (0.5,0) [0|480] "ohm" Vector__XXX
 SG_ MET393_3_5_SI_DRIVE_SW : 29|3@1+ (1,0) [0|7] "" Vector__XXX
 SG_ MET393_2_0_OUTTEMP_FOR_DIAG : 16|13@1+ (0.1,-400) [-400|419.1] "℃"  ACN
 SG_ MET393_1_0_MSG_COUNTER : 8|4@1+ (1,0) [0|15] "" Vector__XXX
 SG_ MET393_1_4_CSTM_IND_BLUE : 12|1@1+ (1,0) [0|1] ""  EAM_HUD
 SG_ MET393_1_5_CSTM_AES_CONT : 13|1@1+ (1,0) [0|1] "" Vector__XXX
 SG_ MET393_1_6_FLG_PEDESTRIAN_AIRBAG : 14|1@1+ (1,0) [0|1] "" Vector__XXX
 SG_ MET393_0_0_CHECK_SUM : 0|8@1+ (1,0) [0|255] ""  ACN

BO_ 912 MET390: 8 C_ECU_GW
 SG_ MET390_7_0_VDC_ON_OFF : 56|2@1+ (1,0) [0|3] "" Vector__XXX
 SG_ MET390_7_2_RR_DOOR_RECORD_L : 58|1@1+ (1,0) [0|1] ""  ACN
 SG_ MET390_7_3_RR_DOOR_RECORD_R : 59|1@1+ (1,0) [0|1] ""  ACN
 SG_ MET390_7_4_REQ_CHG_CSTM_PSM : 60|1@1+ (1,0) [0|1] "" Vector__XXX
 SG_ MET390_7_5_REQ_RESET_CSTM_PSM : 61|1@1+ (1,0) [0|1] "" Vector__XXX
 SG_ MET390_7_6_CSTM_MIR_AFOLD_CONT : 62|1@1+ (1,0) [0|1] "" Vector__XXX
 SG_ MET390_7_7_CSTM_MIR_RTILT_CONT : 63|1@1+ (1,0) [0|1] "" Vector__XXX
 SG_ MET390_6_0_SEATBELT_DRVR : 48|1@1+ (1,0) [0|1] ""  SMT
 SG_ MET390_6_1_SEATBELT_PASS : 49|1@1+ (1,0) [0|1] "" Vector__XXX
 SG_ MET390_6_2_TURN_SIG_LEFT : 50|1@1+ (1,0) [0|1] "" Vector__XXX
 SG_ MET390_6_3_TURN_SIG_RIGHT : 51|1@1+ (1,0) [0|1] "" Vector__XXX
 SG_ MET390_6_4_BRIGHT_SW : 52|1@1+ (1,0) [0|1] ""  EAM_HUD
 SG_ MET390_6_5_FAIL_UART_WA_BOX : 53|1@1+ (1,0) [0|1] "" Vector__XXX
 SG_ MET390_6_6_ISS_OFF_SW : 54|1@1+ (1,0) [0|1] "" Vector__XXX
 SG_ MET390_6_7_FLG_DMS : 55|1@1+ (1,0) [0|1] ""  ACN
 SG_ MET390_5_0_ILL_BRIGHTNESS : 40|8@1+ (0.4,0) [0|100] "%"  SMT,EAM_HUD,BIU
 SG_ MET390_4_0_OUTTEMP_FOR_IND : 32|8@1+ (0.5,-40) [-40|80] "℃"  ACN,BIU
 SG_ MET390_3_0_UNIT_SPEED_TRIP : 24|1@1+ (1,0) [0|1] ""  DKY
 SG_ MET390_3_1_FLG_EYESIGHT : 25|1@1+ (1,0) [0|1] ""  BIU
 SG_ MET390_3_2_FLG_ISS : 26|1@1+ (1,0) [0|1] ""  SMT
 SG_ MET390_3_3_FLG_HEV : 27|1@1+ (1,0) [0|1] ""  BIU
 SG_ MET390_3_4_FLG_IMB : 28|1@1+ (1,0) [0|1] "" Vector__XXX
 SG_ MET390_3_5_TIRE_SIZE : 29|1@1+ (1,0) [0|1] "" Vector__XXX
 SG_ MET390_3_6_FLG_XMODE : 30|2@1+ (1,0) [0|3] "" Vector__XXX
 SG_ MET390_2_0_VEHICLE_SERIES : 16|3@1+ (1,0) [0|7] ""  ACN,BIU
 SG_ MET390_2_3_DESTINATION : 19|4@1+ (1,0) [0|12] ""  SMT,ACN
 SG_ MET390_2_7_PASS_DOOR_RECORD : 23|1@1+ (1,0) [0|1] ""  ACN
 SG_ MET390_1_0_MSG_COUNTER : 8|4@1+ (1,0) [0|15] ""  SMT,ACN,BIU
 SG_ MET390_1_4_WAKE_UP_FRAME : 12|1@1+ (1,0) [0|1] "" Vector__XXX
 SG_ MET390_1_5_REQ_COMM_CONT : 13|1@1+ (1,0) [0|1] "" Vector__XXX
 SG_ MET390_1_6_DMS_ID_SET : 14|1@1+ (1,0) [0|1] "" Vector__XXX
 SG_ MET390_1_7_FAIL_EEPROM : 15|1@1+ (1,0) [0|1] ""  SMT
 SG_ MET390_0_0_CHECK_SUM : 0|8@1+ (1,0) [0|255] ""  SMT,ACN,BIU

BO_ 937 MET3A9: 8 C_ECU_GW
 SG_ MET3A9_3_5_DAY_NIGHT_STATE : 29|1@1+ (1,0) [0|1] ""  EAM_HUD
 SG_ MET3A9_3_0_ILL_LEVEL : 24|5@1+ (1,0) [0|21] "" Vector__XXX
 SG_ MET3A9_2_0_ILL_VALUE : 16|8@1+ (0.4,0) [0|100] "%"  EAM_HUD,BIU
 SG_ MET3A9_1_7_BRIGHT_STATE : 15|1@1+ (1,0) [0|1] ""  EAM_HUD
 SG_ MET3A9_1_6_UI_THEME_STATE : 14|1@1+ (1,0) [0|1] "" Vector__XXX
 SG_ MET3A9_1_0_MSG_COUNTER : 8|4@1+ (1,0) [0|15] ""  EAM_HUD,BIU
 SG_ MET3A9_0_0_CHECKSUM : 0|8@1+ (1,0) [0|255] ""  EAM_HUD,BIU

BO_ 933 MET3A5: 8 C_ECU_GW
 SG_ MET3A5_7_0_INSTCNSP_VAL : 56|10@1+ (0.1,0) [0|99.9] "" Vector__XXX
 SG_ MET3A5_5_0_AVEN_TRIPB_VAL : 40|10@1+ (0.1,0) [0|99.9] "" Vector__XXX
 SG_ MET3A5_3_0_AVEN_TRIPA_VAL : 24|10@1+ (0.1,0) [0|99.9] "" Vector__XXX
 SG_ MET3A5_2_0_E2E_COUNTER : 16|8@1+ (1,0) [0|255] "" Vector__XXX
 SG_ MET3A5_0_0_CRC : 0|16@1+ (1,0) [0|65535] "" Vector__XXX

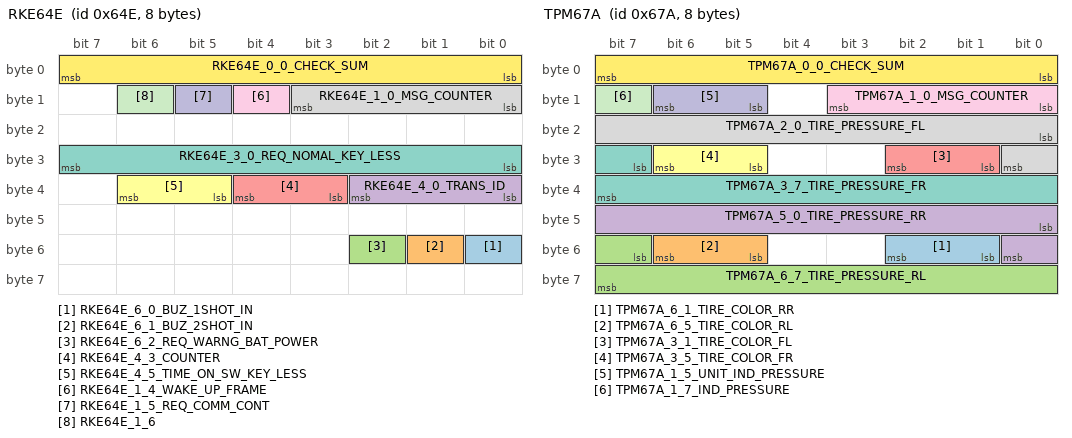
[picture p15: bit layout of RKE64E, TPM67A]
BO_ 1614 RKE64E: 8 TPM
 SG_ RKE64E_6_0_BUZ_1SHOT_IN : 48|1@1+ (1,0) [0|1] ""  C_ECU_GW
 SG_ RKE64E_6_1_BUZ_2SHOT_IN : 49|1@1+ (1,0) [0|1] ""  C_ECU_GW
 SG_ RKE64E_6_2_REQ_WARNG_BAT_POWER : 50|1@1+ (1,0) [0|1] ""  C_ECU_GW
 SG_ RKE64E_4_0_TRANS_ID : 32|3@1+ (1,0) [0|4] ""  C_ECU_GW
 SG_ RKE64E_4_3_COUNTER : 35|2@1+ (1,0) [0|3] ""  BIU,C_ECU_GW
 SG_ RKE64E_4_5_TIME_ON_SW_KEY_LESS : 37|2@1+ (1,0) [0|3] ""  BIU,C_ECU_GW
 SG_ RKE64E_3_0_REQ_NOMAL_KEY_LESS : 24|8@1+ (1,0) [0|8] ""  BIU,C_ECU_GW
 SG_ RKE64E_1_0_MSG_COUNTER : 8|4@1+ (1,0) [0|15] ""  BIU,C_ECU_GW
 SG_ RKE64E_1_4_WAKE_UP_FRAME : 12|1@1+ (1,0) [0|1] ""  C_ECU_GW
 SG_ RKE64E_1_5_REQ_COMM_CONT : 13|1@1+ (1,0) [0|1] ""  C_ECU_GW
 SG_ RKE64E_1_6 : 14|1@1+ (1,0) [0|1] ""  C_ECU_GW
 SG_ RKE64E_0_0_CHECK_SUM : 0|8@1+ (1,0) [0|255] ""  BIU,C_ECU_GW

BO_ 1285 RKE505: 8 TPM
 SG_ RKE505_1_4_ActiveWakeUpBit : 12|1@1+ (1,0) [0|1] ""  PSC,MCR,MCL,PRG,SMT,BIU,C_ECU
 SG_ RKE505_0_0_SourceNodeID : 0|8@1+ (1,0) [0|255] ""  PSC,MCR,MCL,PRG,SMT,BIU,C_ECU

BO_ 1658 TPM67A: 8 TPM
 SG_ TPM67A_6_1_TIRE_COLOR_RR : 49|2@1+ (1,0) [0|3] ""  C_ECU_GW
 SG_ TPM67A_6_5_TIRE_COLOR_RL : 53|2@1+ (1,0) [0|3] ""  C_ECU_GW
 SG_ TPM67A_6_7_TIRE_PRESSURE_RL : 55|9@1+ (1,0) [0|511] ""  C_ECU,C_ECU_GW
 SG_ TPM67A_5_0_TIRE_PRESSURE_RR : 40|9@1+ (1,0) [0|511] ""  C_ECU,C_ECU_GW
 SG_ TPM67A_3_1_TIRE_COLOR_FL : 25|2@1+ (1,0) [0|3] ""  C_ECU_GW
 SG_ TPM67A_3_5_TIRE_COLOR_FR : 29|2@1+ (1,0) [0|3] ""  C_ECU_GW
 SG_ TPM67A_3_7_TIRE_PRESSURE_FR : 31|9@1+ (1,0) [0|511] ""  C_ECU,C_ECU_GW
 SG_ TPM67A_2_0_TIRE_PRESSURE_FL : 16|9@1+ (1,0) [0|511] ""  C_ECU,C_ECU_GW
 SG_ TPM67A_1_0_MSG_COUNTER : 8|4@1+ (1,0) [0|15] ""  C_ECU_GW
 SG_ TPM67A_1_5_UNIT_IND_PRESSURE : 13|2@1+ (1,0) [0|3] ""  C_ECU,C_ECU_GW
 SG_ TPM67A_1_7_IND_PRESSURE : 15|1@1+ (1,0) [0|1] ""  C_ECU_GW
 SG_ TPM67A_0_0_CHECK_SUM : 0|8@1+ (1,0) [0|255] ""  C_ECU_GW

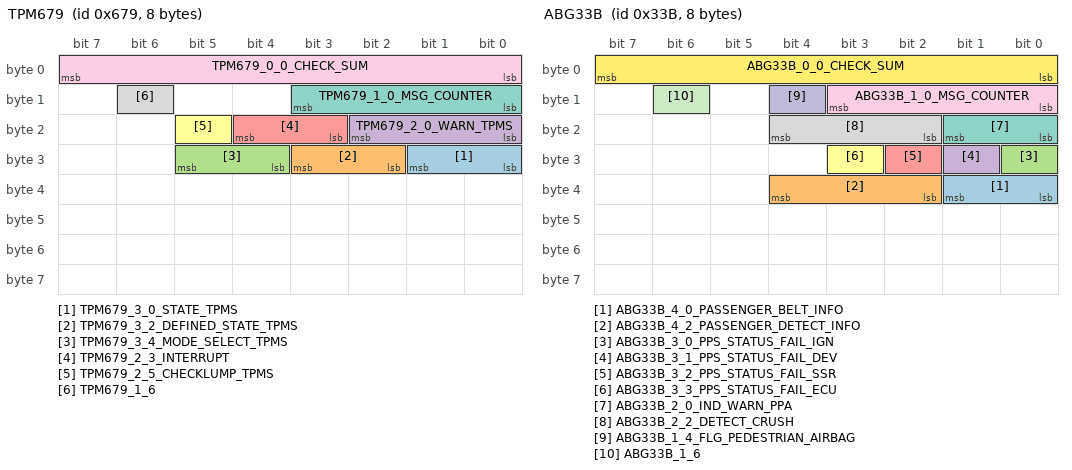
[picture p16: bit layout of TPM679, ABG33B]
BO_ 1657 TPM679: 8 TPM
 SG_ TPM679_3_0_STATE_TPMS : 24|2@1+ (1,0) [0|3] ""  C_ECU_GW
 SG_ TPM679_3_2_DEFINED_STATE_TPMS : 26|2@1+ (1,0) [0|3] ""  C_ECU_GW
 SG_ TPM679_3_4_MODE_SELECT_TPMS : 28|2@1+ (1,0) [0|3] ""  C_ECU_GW
 SG_ TPM679_2_0_WARN_TPMS : 16|3@1+ (1,0) [0|7] ""  C_ECU_GW
 SG_ TPM679_2_3_INTERRUPT : 19|2@1+ (1,0) [0|2] ""  C_ECU_GW
 SG_ TPM679_2_5_CHECKLUMP_TPMS : 21|1@1+ (1,0) [0|1] ""  C_ECU_GW
 SG_ TPM679_1_0_MSG_COUNTER : 8|4@1+ (1,0) [0|15] ""  C_ECU_GW
 SG_ TPM679_1_6 : 14|1@1+ (1,0) [0|1] ""  C_ECU_GW
 SG_ TPM679_0_0_CHECK_SUM : 0|8@1+ (1,0) [0|255] ""  C_ECU_GW

BO_ 827 ABG33B: 8 C_ECU_GW
 SG_ ABG33B_4_0_PASSENGER_BELT_INFO : 32|2@1+ (1,0) [0|3] ""  ACN
 SG_ ABG33B_4_2_PASSENGER_DETECT_INFO : 34|3@1+ (1,0) [0|7] ""  ACN
 SG_ ABG33B_3_0_PPS_STATUS_FAIL_IGN : 24|1@1+ (1,0) [0|1] "" Vector__XXX
 SG_ ABG33B_3_1_PPS_STATUS_FAIL_DEV : 25|1@1+ (1,0) [0|1] "" Vector__XXX
 SG_ ABG33B_3_2_PPS_STATUS_FAIL_SSR : 26|1@1+ (1,0) [0|1] "" Vector__XXX
 SG_ ABG33B_3_3_PPS_STATUS_FAIL_ECU : 27|1@1+ (1,0) [0|1] "" Vector__XXX
 SG_ ABG33B_2_0_IND_WARN_PPA : 16|2@1+ (1,0) [0|3] "" Vector__XXX
 SG_ ABG33B_2_2_DETECT_CRUSH : 18|3@1+ (1,0) [0|7] "" Vector__XXX
 SG_ ABG33B_1_0_MSG_COUNTER : 8|4@1+ (1,0) [0|15] ""  ACN
 SG_ ABG33B_1_4_FLG_PEDESTRIAN_AIRBAG : 12|1@1+ (1,0) [0|1] "" Vector__XXX
 SG_ ABG33B_1_6 : 14|1@1+ (1,0) [0|1] "" Vector__XXX
 SG_ ABG33B_0_0_CHECK_SUM : 0|8@1+ (1,0) [0|255] ""  ACN

BO_ 826 ABG33A: 8 C_ECU_GW
 SG_ ABG33A_7_0_VELOCITYCHANGE_VX_MAX : 56|8@1+ (1,0) [-101|101] "km/h" Vector__XXX
 SG_ ABG33A_6_0_VELOCITYCHANGE_VX_MAX : 48|8@1+ (1,0) [-101|101] "km/h" Vector__XXX
 SG_ ABG33A_5_0_P_SIDE_ABG_DEPLOY : 40|1@1+ (1,0) [0|1] "" Vector__XXX
 SG_ ABG33A_5_1_D_SIDE_ABG_DEPLOY : 41|1@1+ (1,0) [0|1] "" Vector__XXX
 SG_ ABG33A_5_2_FRONT_FAR_ABG_DEPLOY : 42|1@1+ (1,0) [0|1] "" Vector__XXX
 SG_ ABG33A_5_3_REAR_FAR_ABG_DEPLOY : 43|1@1+ (1,0) [0|1] "" Vector__XXX
 SG_ ABG33A_5_4_REAR_RH_ABG_DEPLOY : 44|1@1+ (1,0) [0|1] "" Vector__XXX
 SG_ ABG33A_5_5_REAR_LH_ABG_DEPLOY : 45|1@1+ (1,0) [0|1] "" Vector__XXX
 SG_ ABG33A_5_6_P_CURTAIN_ABG_DEPLOY : 46|1@1+ (1,0) [0|1] "" Vector__XXX
 SG_ ABG33A_5_7_D_CURTAIN_ABG_DEPLOY : 47|1@1+ (1,0) [0|1] "" Vector__XXX
 SG_ ABG33A_4_0_D_FRONT_ABG_DEPLOY : 32|1@1+ (1,0) [0|1] "" Vector__XXX
 SG_ ABG33A_4_1_P_FRONT_ABG_DEPLOY : 33|1@1+ (1,0) [0|1] "" Vector__XXX
 SG_ ABG33A_4_2_P_ABG_DEPLOY : 34|1@1+ (1,0) [0|1] "" Vector__XXX
 SG_ ABG33A_4_3_D_ABG_DEPLOY : 35|1@1+ (1,0) [0|1] "" Vector__XXX
 SG_ ABG33A_4_4_P_BELT_PRETENTION : 36|1@1+ (1,0) [0|1] "" Vector__XXX
 SG_ ABG33A_4_5_D_BELT_PRETENTION : 37|1@1+ (1,0) [0|1] "" Vector__XXX
 SG_ ABG33A_4_6_D_KNEE_ABG_DEPLOY : 38|1@1+ (1,0) [0|1] "" Vector__XXX
 SG_ ABG33A_4_7_P_KNEE_ABG_DEPLOY : 39|1@1+ (1,0) [0|1] "" Vector__XXX
 SG_ ABG33A_3_0_BELT_WRNING_PASS : 24|2@1+ (1,0) [0|3] "" Vector__XXX
 SG_ ABG33A_3_2_BUCKLESW_DRVR : 26|2@1+ (1,0) [0|3] "" Vector__XXX
 SG_ ABG33A_3_4_OCCUPATION_PASS : 28|2@1+ (1,0) [0|3] ""  BIU
 SG_ ABG33A_3_6_IND_ACT_ABG_PASS : 30|2@1+ (1,0) [0|3] "" Vector__XXX
 SG_ ABG33A_2_0_IND_WARN_ABG : 16|2@1+ (1,0) [0|3] "" Vector__XXX
 SG_ ABG33A_2_2_DETECT_CRUSH : 18|3@1+ (1,0) [0|7] ""  PRG,SMT
 SG_ ABG33A_2_5_STATUS_CRUSH_ECALL : 21|3@1+ (1,0) [0|7] "" Vector__XXX
 SG_ ABG33A_1_0_MSG_COUNTER : 8|4@1+ (1,0) [0|15] ""  PRG,SMT
 SG_ ABG33A_1_4_FLG_ABGIND_CTRL : 12|1@1+ (1,0) [0|1] "" Vector__XXX
 SG_ ABG33A_1_5_REQ_COMM_CONT : 13|1@1+ (1,0) [0|1] "" Vector__XXX
 SG_ ABG33A_1_6_COLLISION_COUNTER : 14|2@1+ (1,0) [0|3] "" Vector__XXX
 SG_ ABG33A_0_0_CHECK_SUM : 0|8@1+ (1,0) [0|255] ""  PRG,SMT

BO_ 961 DMS3C1: 8 C_ECU_GW
 SG_ DMS3C1_7_4_SHORT_DIST_DETECT : 60|1@1+ (1,0) [0|1] "" Vector__XXX
 SG_ DMS3C1_7_5_PRESENCE_DETECT : 61|1@1+ (1,0) [0|1] "" Vector__XXX
 SG_ DMS3C1_7_6_RADER_EQUIP : 62|1@1+ (1,0) [0|1] "" Vector__XXX
 SG_ DMS3C1_7_7_LOSING_POSTURE_DETECT : 63|1@1+ (1,0) [0|1] "" Vector__XXX
 SG_ DMS3C1_6_0_ID_RECOG_CANCEL : 48|1@1+ (1,0) [0|1] "" Vector__XXX
 SG_ DMS3C1_6_1_ID_ENABLE_FLAG : 49|1@1+ (1,0) [0|1] "" Vector__XXX
 SG_ DMS3C1_6_2_PERMIT_AVN_FLAG : 50|1@1+ (1,0) [0|1] "" Vector__XXX
 SG_ DMS3C1_6_4_DISTRACTION_STATUS : 52|1@1+ (1,0) [0|1] "" Vector__XXX
 SG_ DMS3C1_6_5_DROWSINESS_STATUS : 53|1@1+ (1,0) [0|1] "" Vector__XXX
 SG_ DMS3C1_6_6_DROWSINESS_LV2_STATUS : 54|1@1+ (1,0) [0|1] "" Vector__XXX
 SG_ DMS3C1_6_7_NOT_DETECTED_STATUS : 55|1@1+ (1,0) [0|1] "" Vector__XXX
 SG_ DMS3C1_5_0_ID_LIST : 40|5@1+ (1,0) [0|31] "" Vector__XXX
 SG_ DMS3C1_5_5_ID_EDIT_FLAG : 45|3@1+ (1,0) [0|6] "" Vector__XXX
 SG_ DMS3C1_4_0_DMS_IND_REQ_FLAG : 32|3@1+ (1,0) [0|7] "" Vector__XXX
 SG_ DMS3C1_4_3_DMS_RECOG_STATUS : 35|1@1+ (1,0) [0|1] "" Vector__XXX
 SG_ DMS3C1_4_4_DRIVER_STATUS : 36|4@1+ (1,0) [0|3] "" Vector__XXX
 SG_ DMS3C1_3_0_DRIVER_REGIST_ID : 24|4@1+ (1,0) [0|15] "" Vector__XXX
 SG_ DMS3C1_3_4_CUST_EDIT_FLAG : 28|2@1+ (1,0) [0|3] "" Vector__XXX
 SG_ DMS3C1_3_6_ID_RECOG_FLAG : 30|1@1+ (1,0) [0|1] "" Vector__XXX
 SG_ DMS3C1_2_0_LEVEL_DROWS : 16|3@1+ (1,0) [0|2] "" Vector__XXX
 SG_ DMS3C1_2_3_DROWS_DETECT_FLAG : 19|1@1+ (1,0) [0|1] "" Vector__XXX
 SG_ DMS3C1_2_7_DIST_DETECT_FLAG : 23|1@1+ (1,0) [0|1] "" Vector__XXX
 SG_ DMS3C1_1_0_MSG_COUNTER : 8|4@1+ (1,0) [0|15] "" Vector__XXX
 SG_ DMS3C1_1_4_WAKE_UP_FRAME : 12|1@1+ (1,0) [0|1] "" Vector__XXX
 SG_ DMS3C1_1_5_REQ_COMM_CONT : 13|1@1+ (1,0) [0|1] "" Vector__XXX
 SG_ DMS3C1_1_7_EYE_DIST_FLAG : 15|1@1+ (1,0) [0|1] "" Vector__XXX
 SG_ DMS3C1_0_0_CHKSUM : 0|8@1+ (1,0) [0|255] "" Vector__XXX

BO_ 1651 ACN673: 8 ACN
 SG_ ACN673_7_2_REQ_STRG_H : 58|2@1+ (1,0) [0|3] ""  C_ECU_GW
 SG_ ACN673_7_1_SEAT_H_L_AUTOIND : 57|1@1+ (1,0) [0|1] ""  C_ECU_GW
 SG_ ACN673_7_0_SEAT_H_R_AUTOIND : 56|1@1+ (1,0) [0|1] ""  C_ECU_GW
 SG_ ACN673_6_0_RR_FAN_SYMBOL : 48|1@1+ (1,0) [0|1] ""  C_ECU_GW
 SG_ ACN673_6_2_SEAT_H_R : 50|3@1+ (1,0) [0|7] ""  C_ECU_GW
 SG_ ACN673_6_5_SEAT_H_L : 53|3@1+ (1,0) [0|7] ""  C_ECU_GW
 SG_ ACN673_5_0_DR_ONLY : 40|2@1+ (1,0) [0|3] ""  C_ECU_GW
 SG_ ACN673_5_2_STRG_H : 42|2@1+ (1,0) [0|3] ""  C_ECU_GW
 SG_ ACN673_5_4_AC_SI_DS_SET : 44|2@1+ (1,0) [0|3] ""  C_ECU_GW
 SG_ ACN673_5_6_STRG_H_AUTOIND : 46|1@1+ (1,0) [0|1] ""  C_ECU_GW
 SG_ ACN673_5_7_AC_SI_DS_FLG : 47|1@1+ (1,0) [0|1] ""  C_ECU_GW
 SG_ ACN673_4_0_SEAT_HEATER_DR : 32|2@1+ (1,0) [0|3] ""  C_ECU_GW
 SG_ ACN673_4_2_SEAT_HEATER_PA : 34|2@1+ (1,0) [0|3] ""  C_ECU_GW
 SG_ ACN673_4_4_SEAT_HEATER : 36|1@1+ (1,0) [0|1] ""  C_ECU_GW
 SG_ ACN673_4_5_TEMP_SET_TYPE : 37|2@1+ (1,0) [0|3] ""  C_ECU_GW
 SG_ ACN673_4_7_VENTI_SEAT_EX_HI : 39|1@1+ (1,0) [0|1] ""  C_ECU_GW
 SG_ ACN673_1_0_MSG_COUNTER : 8|4@1+ (1,0) [0|15] ""  C_ECU_GW
 SG_ ACN673_1_6_SYNC_RR : 14|1@1+ (1,0) [0|1] ""  C_ECU_GW
 SG_ ACN673_1_7_RR_LOCK : 15|1@1+ (1,0) [0|1] ""  C_ECU_GW
 SG_ ACN673_0_0_CHECK_SUM : 0|8@1+ (1,0) [0|255] ""  C_ECU_GW

BO_ 1650 ACN672: 8 ACN
 SG_ ACN672_7_0_INFO_AUTO3MODE : 56|2@1+ (1,0) [0|3] ""  C_ECU_GW
 SG_ ACN672_7_2_INFO_REAR_TEMP : 58|6@1+ (1,0) [0|44] ""  C_ECU_GW
 SG_ ACN672_6_0_DEF : 48|1@1+ (1,0) [0|1] ""  C_ECU_GW
 SG_ ACN672_6_1_FAN_SYMBOL : 49|1@1+ (1,0) [0|1] ""  C_ECU,C_ECU_GW
 SG_ ACN672_6_2_REAR_MODE : 50|2@1+ (1,0) [0|3] ""  C_ECU_GW
 SG_ ACN672_6_4_UNIT_TEMP : 52|1@1+ (1,0) [0|1] ""  C_ECU_GW
 SG_ ACN672_6_5_SPEC_AC_UNIT : 53|2@1+ (1,0) [0|3] ""  C_ECU_GW
 SG_ ACN672_6_7_REAR_AC : 55|1@1+ (1,0) [0|1] ""  C_ECU_GW
 SG_ ACN672_5_0_AC_VR_MODE : 40|2@1+ (1,0) [0|3] ""  C_ECU_GW
 SG_ ACN672_5_2_INFO_TEMP_PASS : 42|6@1+ (1,0) [0|63] ""  C_ECU_GW
 SG_ ACN672_4_0_AC_INTERRUPT_DISPLAY : 32|1@1+ (1,0) [0|1] ""  C_ECU_GW
 SG_ ACN672_4_1_AC_VR_ACTION : 33|1@1+ (1,0) [0|1] ""  C_ECU_GW
 SG_ ACN672_4_2_INFO_TEMP_DRVR : 34|6@1+ (1,0) [0|63] ""  C_ECU_GW
 SG_ ACN672_3_0_MAX_AC : 24|1@1+ (1,0) [0|1] ""  C_ECU_GW
 SG_ ACN672_3_1_INFO_SYNC_OR_SING : 25|1@1+ (1,0) [0|1] ""  C_ECU_GW
 SG_ ACN672_3_2_INFO_FULL_OR_AUTO : 26|2@1+ (1,0) [0|3] ""  C_ECU_GW
 SG_ ACN672_3_4_INFO_AC_ON : 28|1@1+ (1,0) [0|1] ""  C_ECU_GW
 SG_ ACN672_3_5_INFO_RDEF : 29|1@1+ (1,0) [0|1] ""  C_ECU_GW
 SG_ ACN672_3_6_INFO_CIRCULATION : 30|2@1+ (1,0) [0|3] ""  C_ECU_GW
 SG_ ACN672_2_0_INFO_MODE_VENT : 16|4@1+ (1,0) [0|15] ""  C_ECU_GW
 SG_ ACN672_2_4_INFO_FANONLY : 20|1@1+ (1,0) [0|1] ""  C_ECU_GW
 SG_ ACN672_2_5_INFO_LEV_BLOWERFAN : 21|3@1+ (1,0) [0|7] ""  C_ECU_GW
 SG_ ACN672_1_0_MSG_COUNTER : 8|4@1+ (1,0) [0|15] ""  C_ECU,C_ECU_GW
 SG_ ACN672_1_4_LVL_BLOWERFAN_RR : 12|3@1+ (1,0) [0|7] ""  C_ECU_GW
 SG_ ACN672_1_7_REAR_AUTO : 15|1@1+ (1,0) [0|1] ""  C_ECU_GW
 SG_ ACN672_0_0_CHECK_SUM : 0|8@1+ (1,0) [0|255] ""  C_ECU,C_ECU_GW

BO_ 722 ACN2D2: 8 ACN
 SG_ ACN2D2_7_0_PD_PRESSURE : 56|8@1+ (0.0146866,0) [0|3.74509] "Mpa"  C_ECU_GW
 SG_ ACN2D2_6_0_TRQ_COMP_ESTM : 48|8@1+ (0.3921568627451,0) [0|100] "Nm"  C_ECU_GW
 SG_ ACN2D2_5_0_REQ_ENG_RPM : 40|3@1+ (1,0) [0|6] ""  C_ECU_GW
 SG_ ACN2D2_5_3_REQ_IDLE_COMP_RPM : 43|5@1+ (25,650) [650|1425] "rpm"  C_ECU_GW
 SG_ ACN2D2_4_0_LVL_PTC : 32|2@1+ (1,0) [0|3] ""  C_ECU_GW
 SG_ ACN2D2_4_2_MARGIN_OF_AC : 34|3@1+ (1,0) [0|7] ""  C_ECU_GW
 SG_ ACN2D2_4_5_LVL_BLOWER_FAN : 37|3@1+ (1,0) [0|7] ""  C_ECU_GW
 SG_ ACN2D2_3_0_PERMIT_ISS : 24|2@1+ (1,0) [0|3] ""  C_ECU_GW
 SG_ ACN2D2_3_2_TRQ_PAT_COMP_ESTM : 26|3@1+ (1,0) [0|6] ""  C_ECU_GW
 SG_ ACN2D2_3_5_IND_ROOM_TEMP : 29|3@1+ (1,0) [0|4] ""  C_ECU_GW
 SG_ ACN2D2_2_0_FAIL_TRQ_COMP_ESTM : 16|1@1+ (1,0) [0|1] ""  C_ECU_GW
 SG_ ACN2D2_2_1_FAIL_AC : 17|1@1+ (1,0) [0|1] ""  C_ECU_GW
 SG_ ACN2D2_2_2_REQ_INHIBIT_LOCKUP : 18|1@1+ (1,0) [0|1] ""  C_ECU_GW
 SG_ ACN2D2_2_3_AC_ON : 19|1@1+ (1,0) [0|1] ""  C_ECU_GW
 SG_ ACN2D2_2_4_RDEFOGSW : 20|1@1+ (1,0) [0|1] ""  BIU,C_ECU_GW
 SG_ ACN2D2_2_5_WARM_UP : 21|1@1+ (1,0) [0|1] ""  C_ECU_GW
 SG_ ACN2D2_2_6_AC_AUTO_MANUAL : 22|1@1+ (1,0) [0|1] ""  C_ECU_GW
 SG_ ACN2D2_2_7_COMP_TYPE : 23|1@1+ (1,0) [0|1] ""  C_ECU_GW
 SG_ ACN2D2_1_0_MSG_COUNTER : 8|4@1+ (1,0) [0|15] ""  BIU,C_ECU_GW
 SG_ ACN2D2_1_4 : 12|1@1+ (1,0) [0|1] ""  C_ECU_GW
 SG_ ACN2D2_1_5 : 13|1@1+ (1,0) [0|1] ""  C_ECU_GW
 SG_ ACN2D2_1_6 : 14|1@1+ (1,0) [0|1] ""  C_ECU_GW
 SG_ ACN2D2_1_7_WARM_POWER_CONT : 15|1@1+ (1,0) [0|1] ""  C_ECU_GW
 SG_ ACN2D2_0_0_CHECK_SUM : 0|8@1+ (1,0) [0|255] ""  BIU,C_ECU_GW

BO_ 1373 ACN55D: 8 ACN
 SG_ ACN55D_7_0_NETWORK_STATUS : 7|64@0+ (1,0) [0|0] ""  C_ECU

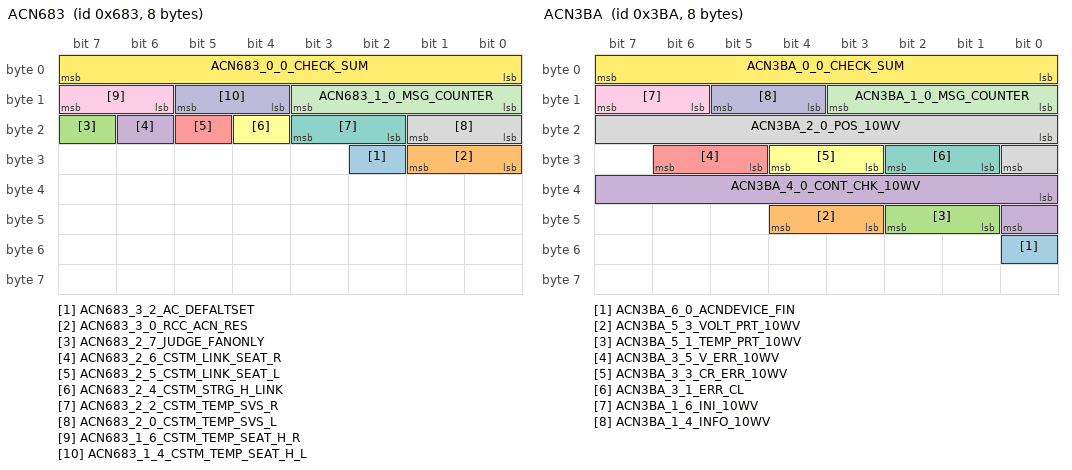
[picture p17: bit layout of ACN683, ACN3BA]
BO_ 1667 ACN683: 8 ACN
 SG_ ACN683_3_2_AC_DEFALTSET : 26|1@1+ (1,0) [0|1] ""  C_ECU_GW
 SG_ ACN683_3_0_RCC_ACN_RES : 24|2@1+ (1,0) [0|3] ""  C_ECU,C_ECU_GW
 SG_ ACN683_2_7_JUDGE_FANONLY : 23|1@1+ (1,0) [0|1] ""  C_ECU_GW
 SG_ ACN683_2_6_CSTM_LINK_SEAT_R : 22|1@1+ (1,0) [0|1] ""  C_ECU_GW
 SG_ ACN683_2_5_CSTM_LINK_SEAT_L : 21|1@1+ (1,0) [0|1] ""  C_ECU_GW
 SG_ ACN683_2_4_CSTM_STRG_H_LINK : 20|1@1+ (1,0) [0|1] ""  C_ECU_GW
 SG_ ACN683_2_2_CSTM_TEMP_SVS_R : 18|2@1+ (1,0) [0|3] ""  C_ECU_GW
 SG_ ACN683_2_0_CSTM_TEMP_SVS_L : 16|2@1+ (1,0) [0|3] ""  C_ECU_GW
 SG_ ACN683_1_6_CSTM_TEMP_SEAT_H_R : 14|2@1+ (1,0) [0|3] ""  C_ECU_GW
 SG_ ACN683_1_4_CSTM_TEMP_SEAT_H_L : 12|2@1+ (1,0) [0|3] ""  C_ECU_GW
 SG_ ACN683_1_0_MSG_COUNTER : 8|4@1+ (1,0) [0|15] ""  C_ECU,C_ECU_GW
 SG_ ACN683_0_0_CHECK_SUM : 0|8@1+ (1,0) [0|255] ""  C_ECU,C_ECU_GW

BO_ 957 ACN3BD: 8 ACN
 SG_ ACN3BD_4_0_STATE_HT_ACT : 32|2@1+ (1,0) [0|3] ""  C_ECU_GW
 SG_ ACN3BD_3_3_STATE_HT_CIR : 27|4@1+ (1,0) [0|4] ""  C_ECU_GW
 SG_ ACN3BD_3_0_STATE_HT_CIR_SW : 24|3@1+ (1,0) [0|4] ""  C_ECU_GW
 SG_ ACN3BD_2_0_POS_4WV : 16|9@1+ (1,0) [0|360] "deg"  C_ECU_GW
 SG_ ACN3BD_1_4_ERR_HTDEV : 12|3@1+ (1,0) [0|7] ""  C_ECU_GW
 SG_ ACN3BD_1_0_MSG_COUNTER : 8|4@1+ (1,0) [0|15] ""  C_ECU_GW
 SG_ ACN3BD_0_0_CHECK_SUM : 0|8@1+ (1,0) [0|255] ""  C_ECU_GW

BO_ 954 ACN3BA: 8 ACN
 SG_ ACN3BA_6_0_ACNDEVICE_FIN : 48|1@1+ (1,0) [0|1] ""  C_ECU_GW
 SG_ ACN3BA_5_3_VOLT_PRT_10WV : 43|2@1+ (1,0) [0|3] ""  C_ECU_GW
 SG_ ACN3BA_5_1_TEMP_PRT_10WV : 41|2@1+ (1,0) [0|3] ""  C_ECU_GW
 SG_ ACN3BA_4_0_CONT_CHK_10WV : 32|9@1+ (1,0) [0|360] "deg"  C_ECU_GW
 SG_ ACN3BA_3_5_V_ERR_10WV : 29|2@1+ (1,0) [0|3] ""  C_ECU_GW
 SG_ ACN3BA_3_3_CR_ERR_10WV : 27|2@1+ (1,0) [0|3] ""  C_ECU_GW
 SG_ ACN3BA_3_1_ERR_CL : 25|2@1+ (1,0) [0|3] ""  C_ECU_GW
 SG_ ACN3BA_2_0_POS_10WV : 16|9@1+ (1,0) [0|360] "deg"  C_ECU_GW
 SG_ ACN3BA_1_6_INI_10WV : 14|2@1+ (1,0) [0|3] ""  C_ECU_GW
 SG_ ACN3BA_1_4_INFO_10WV : 12|2@1+ (1,0) [0|3] ""  C_ECU_GW
 SG_ ACN3BA_1_0_MSG_COUNTER : 8|4@1+ (1,0) [0|15] ""  C_ECU_GW
 SG_ ACN3BA_0_0_CHECK_SUM : 0|8@1+ (1,0) [0|255] ""  C_ECU_GW

BO_ 1659 ACN67B: 8 ACN
 SG_ ACN67B_6_0_STATE_INW : 48|1@1+ (1,0) [0|1] ""  C_ECU_GW
 SG_ ACN67B_5_2_JUDGE_OIL_SALVAGE : 42|2@1+ (1,0) [0|3] ""  C_ECU_GW
 SG_ ACN67B_5_0_OIL_SALVAGE_READY : 40|1@1+ (1,0) [0|1] ""  C_ECU_GW
 SG_ ACN67B_4_3_STATE_ACLOAD : 35|3@1+ (1,0) [0|7] ""  C_ECU_GW
 SG_ ACN67B_4_2_REQ_LT_DEF : 34|1@1+ (1,0) [0|1] ""  C_ECU_GW
 SG_ ACN67B_4_1_REQ_HT_RAD : 33|1@1+ (1,0) [0|1] ""  C_ECU_GW
 SG_ ACN67B_4_0_STATE_BATHP : 32|1@1+ (1,0) [0|1] ""  C_ECU_GW
 SG_ ACN67B_3_4_REQ_ACCYC : 28|3@1+ (1,0) [0|4] ""  C_ECU_GW
 SG_ ACN67B_3_3_JUDGE_AMBHP : 27|1@1+ (1,0) [0|1] ""  C_ECU_GW
 SG_ ACN67B_3_1_RL_LTO : 25|2@1+ (1,0) [0|3] ""  C_ECU_GW
 SG_ ACN67B_2_0_TW_LTO : 16|9@1+ (0.5,-40) [-40|215.5] "℃"  C_ECU_GW
 SG_ ACN67B_1_7_JUDGE_LTHP : 15|1@1+ (1,0) [0|1] ""  C_ECU_GW
 SG_ ACN67B_1_6_HTS_BAT_COMB : 14|1@1+ (1,0) [0|1] ""  C_ECU_GW
 SG_ ACN67B_1_5_HTS_AC_ALONE : 13|1@1+ (1,0) [0|1] ""  C_ECU_GW
 SG_ ACN67B_1_4_PERMIT_TL : 12|1@1+ (1,0) [0|1] ""  C_ECU_GW
 SG_ ACN67B_1_0_MSG_COUNTER : 8|4@1+ (1,0) [0|15] ""  C_ECU_GW
 SG_ ACN67B_0_0_CHECK_SUM : 0|8@1+ (1,0) [0|255] ""  C_ECU_GW

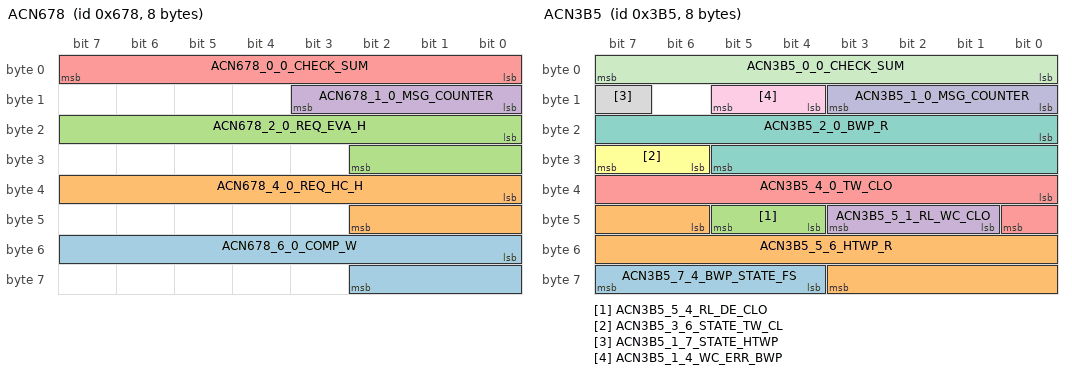
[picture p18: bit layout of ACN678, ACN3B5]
BO_ 1656 ACN678: 8 ACN
 SG_ ACN678_6_0_COMP_W : 48|11@1+ (10,0) [0|20470] "W"  C_ECU_GW
 SG_ ACN678_4_0_REQ_HC_H : 32|11@1+ (10,0) [0|20470] "W"  C_ECU_GW
 SG_ ACN678_2_0_REQ_EVA_H : 16|11@1+ (10,0) [0|20470] "W"  C_ECU_GW
 SG_ ACN678_1_0_MSG_COUNTER : 8|4@1+ (1,0) [0|15] ""  C_ECU_GW
 SG_ ACN678_0_0_CHECK_SUM : 0|8@1+ (1,0) [0|255] ""  C_ECU_GW

BO_ 949 ACN3B5: 8 ACN
 SG_ ACN3B5_7_4_BWP_STATE_FS : 60|4@1+ (1,0) [0|12] ""  C_ECU_GW
 SG_ ACN3B5_5_6_HTWP_R : 46|14@1+ (1,0) [0|16383] "RPM"  C_ECU_GW
 SG_ ACN3B5_5_4_RL_DE_CLO : 44|2@1+ (1,0) [0|3] ""  C_ECU_GW
 SG_ ACN3B5_5_1_RL_WC_CLO : 41|3@1+ (1,0) [0|7] ""  C_ECU_GW
 SG_ ACN3B5_4_0_TW_CLO : 32|9@1+ (0.5,-40) [-40|215.5] "℃"  C_ECU_GW
 SG_ ACN3B5_3_6_STATE_TW_CL : 30|2@1+ (1,0) [0|3] ""  C_ECU_GW
 SG_ ACN3B5_2_0_BWP_R : 16|14@1+ (1,0) [0|65535] "rpm"  C_ECU_GW
 SG_ ACN3B5_1_7_STATE_HTWP : 15|1@1+ (1,0) [0|1] ""  C_ECU_GW
 SG_ ACN3B5_1_4_WC_ERR_BWP : 12|2@1+ (1,0) [0|3] ""  C_ECU_GW
 SG_ ACN3B5_1_0_MSG_COUNTER : 8|4@1+ (1,0) [0|15] ""  C_ECU_GW
 SG_ ACN3B5_0_0_CHECK_SUM : 0|8@1+ (1,0) [0|255] ""  C_ECU_GW

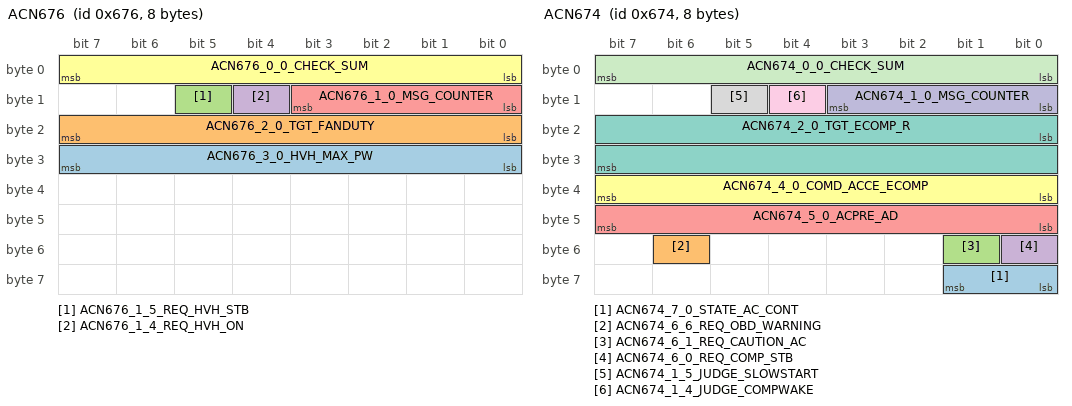
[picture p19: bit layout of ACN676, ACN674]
BO_ 1654 ACN676: 8 ACN
 SG_ ACN676_3_0_HVH_MAX_PW : 24|8@1+ (40,0) [0|10200] "W"  C_ECU_GW
 SG_ ACN676_2_0_TGT_FANDUTY : 16|8@1+ (0.4,0) [0|100] "％"  C_ECU_GW
 SG_ ACN676_1_5_REQ_HVH_STB : 13|1@1+ (1,0) [0|1] ""  C_ECU_GW
 SG_ ACN676_1_4_REQ_HVH_ON : 12|1@1+ (1,0) [0|1] ""  C_ECU_GW
 SG_ ACN676_1_0_MSG_COUNTER : 8|4@1+ (1,0) [0|15] ""  C_ECU_GW
 SG_ ACN676_0_0_CHECK_SUM : 0|8@1+ (1,0) [0|255] ""  C_ECU_GW

BO_ 1652 ACN674: 8 ACN
 SG_ ACN674_7_0_STATE_AC_CONT : 56|2@1+ (1,0) [0|3] ""  C_ECU_GW
 SG_ ACN674_6_6_REQ_OBD_WARNING : 54|1@1+ (1,0) [0|1] ""  C_ECU_GW
 SG_ ACN674_6_1_REQ_CAUTION_AC : 49|1@1+ (1,0) [0|1] ""  C_ECU_GW
 SG_ ACN674_6_0_REQ_COMP_STB : 48|1@1+ (1,0) [0|1] ""  C_ECU_GW
 SG_ ACN674_5_0_ACPRE_AD : 40|8@1+ (0.01953,0) [0|4.9815] "V"  C_ECU_GW
 SG_ ACN674_4_0_COMD_ACCE_ECOMP : 32|8@1+ (20,0) [0|5100] "rpm/s"  C_ECU_GW
 SG_ ACN674_2_0_TGT_ECOMP_R : 16|16@1+ (1,0) [0|65535] "rpm"  C_ECU_GW
 SG_ ACN674_1_5_JUDGE_SLOWSTART : 13|1@1+ (1,0) [0|1] ""  C_ECU_GW
 SG_ ACN674_1_4_JUDGE_COMPWAKE : 12|1@1+ (1,0) [0|1] ""  C_ECU_GW
 SG_ ACN674_1_0_MSG_COUNTER : 8|4@1+ (1,0) [0|15] ""  C_ECU_GW
 SG_ ACN674_0_0_CHECK_SUM : 0|8@1+ (1,0) [0|255] ""  C_ECU_GW

CM_ SG_ 1511 EAM5E7_7_0_DATA "ﾃﾞｰﾀ
";
CM_ SG_ 552 RDR228_7_0_EYE_TIMEOUT_ERROR_FLG "後側方ﾚｰﾀﾞ ｱｲｻｲﾄﾃﾞｰﾀ未着・異常検知ﾌﾗｸﾞ
";
CM_ SG_ 552 RDR228_7_1_BLOCKAGE_FORMING_2 "ﾌﾞﾛｯｹｰｼﾞ2条件成立ﾌﾗｸﾞ
";
CM_ SG_ 552 RDR228_7_2_WARN_LCA_R_1ST "右側LCA警報1次ﾌﾗｸﾞ（注意喚起）
";
CM_ SG_ 552 RDR228_7_3_WARN_LCA_L_1ST "左側LCA警報1次ﾌﾗｸﾞ（注意喚起）
";
CM_ SG_ 552 RDR228_7_4_WARN_LCA_R_2ND "右側LCA警報2次ﾌﾗｸﾞ（ｳｨﾝｶｰON）
";
CM_ SG_ 552 RDR228_7_5_WARN_LCA_L_2ND "左側LCA警報2次ﾌﾗｸﾞ（ｳｨﾝｶｰON）
";
CM_ SG_ 552 RDR228_7_6_WARN_RCTA_R "右RCTA警報ﾌﾗｸﾞ
";
CM_ SG_ 552 RDR228_7_7_WARN_RCTA_L "左RCTA警報ﾌﾗｸﾞ
";
CM_ SG_ 552 RDR228_6_0_WARN_BSD_R_1ST "右側BSD警報ﾌﾗｸﾞ(注意喚起)
";
CM_ SG_ 552 RDR228_6_1_WARN_BSD_L_1ST "左側BSD警報ﾌﾗｸﾞ(注意喚起)
";
CM_ SG_ 552 RDR228_6_2_WARN_BSD_R_2ND "右側BSD警報2次ﾌﾗｸﾞ(ｳｨﾝｶｰON)
";
CM_ SG_ 552 RDR228_6_3_WARN_BSD_L_2ND "左側BSD警報2次ﾌﾗｸﾞ(ｳｨﾝｶｰON)
";
CM_ SG_ 552 RDR228_6_5_BLOCKAGE_STS "ﾌﾞﾛｯｹｰｼﾞｽﾃｰﾀｽ
";
CM_ SG_ 552 RDR228_5_0_BSD_R_E "右側BSDﾌﾗｸﾞ(EYE-ELK用)
";
CM_ SG_ 552 RDR228_5_1_BSD_L_E "左側BSDﾌﾗｸﾞ(EYE-ELK用)
";
CM_ SG_ 552 RDR228_5_2_LCA_R_E "右側LCAﾌﾗｸﾞ(EYE-ELK用)
";
CM_ SG_ 552 RDR228_5_3_LCA_L_E "左側LCAﾌﾗｸﾞ(EYE-ELK用)
";
CM_ SG_ 552 RDR228_5_4_BSD_R_A "右側BSDﾌﾗｸﾞ(EYE-AES用)
";
CM_ SG_ 552 RDR228_5_5_BSD_L_A "左側BSDﾌﾗｸﾞ(EYE-AES用)
";
CM_ SG_ 552 RDR228_5_6_LCA_R_A "右側LCAﾌﾗｸﾞ(EYE-AES用)
";
CM_ SG_ 552 RDR228_5_7_LCA_L_A "左側LCAﾌﾗｸﾞ(EYE-AES用)
";
CM_ SG_ 552 RDR228_4_0_DOW_ACTIVELAMP "DOW Active灯表示ﾌﾗｸﾞ
";
CM_ SG_ 552 RDR228_4_1_WARN_DOW_1ST_R "右側DOW警報1次ﾌﾗｸﾞ
";
CM_ SG_ 552 RDR228_4_2_WARN_DOW_1ST_L "左側DOW警報1次ﾌﾗｸﾞ
";
CM_ SG_ 552 RDR228_4_3_WARN_DOW_2ST_R "右側DOW警報2次ﾌﾗｸﾞ
";
CM_ SG_ 552 RDR228_4_4_WARN_DOW_2ST_L "左側DOW警報2次ﾌﾗｸﾞ
";
CM_ SG_ 552 RDR228_4_5_CSTM_STS_SRVD "ｶｽﾀﾏｲｽﾞ状態－BSD/LCA警報ON-OFF
";
CM_ SG_ 552 RDR228_4_6_CSTM_STS_BSD_LCA_2ND "ｶｽﾀﾏｲｽﾞ状態－BSD/LCA2次ﾌﾞｻﾞｰON-OFF
";
CM_ SG_ 552 RDR228_4_7_CSTM_STS_RCTA "ｶｽﾀﾏｲｽﾞ状態－RCTA　ON-OFF
";
CM_ SG_ 552 RDR228_3_0_WARN_BSD_LCA_R_2ND "右側BSD/LCA2次ﾌﾞｻﾞｰﾌﾗｸﾞ
";
CM_ SG_ 552 RDR228_3_1_WARN_BSD_LCA_L_2ND "左側BSD/LCA2次ﾌﾞｻﾞｰﾌﾗｸﾞ
";
CM_ SG_ 552 RDR228_3_2_CSTM_STS_DOW "ｶｽﾀﾏｲｽﾞ状態－DOW　ON-OFF
";
CM_ SG_ 552 RDR228_3_3_CSTM_STS_DOW_SFT_POS "ｶｽﾀﾏｲｽﾞ状態－DOW有効ｼﾌﾄﾎﾟｼﾞｼｮﾝ
";
CM_ SG_ 552 RDR228_3_5_CSTM_DSP_BSD_LCA "ｶｽﾀﾏｲｽﾞ表示有効－BSD/LCA警報
";
CM_ SG_ 552 RDR228_3_6_CSTM_DSP_BSD_LCA_2ND "ｶｽﾀﾏｲｽﾞ表示有効－BSD/LCA2次ﾌﾞｻﾞｰ
";
CM_ SG_ 552 RDR228_3_7_CSTM_DSP_RCTA "ｶｽﾀﾏｲｽﾞ表示有効－RCTA
";
CM_ SG_ 552 RDR228_2_0_CSTM_DSP_DOW "ｶｽﾀﾏｲｽﾞ表示有効－DOW
";
CM_ SG_ 552 RDR228_2_1_EYE_LOCAL_BUS1_FAIL "後側方ﾚｰﾀﾞ ｱｲｻｲﾄﾛｰｶﾙBUS1異常検知ﾌﾗｸﾞ
";
CM_ SG_ 552 RDR228_2_2_CSTM_DSP_DOW_SFT_POS "ｶｽﾀﾏｲｽﾞ表示有効－DOW有効ｼﾌﾄﾎﾟｼﾞｼｮﾝ
";
CM_ SG_ 552 RDR228_2_3_ELK_STOP_REQ_FLG "後側方ﾚｰﾀﾞELK停止要求ﾌﾗｸﾞ
";
CM_ SG_ 552 RDR228_2_4_FAIL_RDRSYS "後側方ﾚｰﾀﾞｼｽﾃﾑﾌｪｰﾙﾌﾗｸﾞ
";
CM_ SG_ 552 RDR228_2_5_STOP_RDRSYS "後側方ﾚｰﾀﾞｼｽﾃﾑ一時停止ﾌﾗｸﾞ
";
CM_ SG_ 552 RDR228_2_6_ON_OFF_RDRSYS "後側方ﾚｰﾀﾞｼｽﾃﾑON-OFFﾌﾗｸﾞ
";
CM_ SG_ 552 RDR228_2_7_BLOCKAGE_FORMING "ﾌﾞﾛｯｹｰｼﾞ条件成立ﾌﾗｸﾞ
";
CM_ SG_ 552 RDR228_1_0_MSG_COUNTER "ﾒｯｾｰｼﾞｶｳﾝﾀ
";
CM_ SG_ 552 RDR228_1_4_BATT_OFF_CAUSE "DOW電源OFF要求ﾌﾗｸﾞ
";
CM_ SG_ 552 RDR228_1_5_CSTM_GLO_1 "ｶｽﾀﾏｲｽﾞ表示ｸﾞﾚｰｱｳﾄ－1
";
CM_ SG_ 552 RDR228_1_6_CSTM_GLO_3 "ｶｽﾀﾏｲｽﾞ表示ｸﾞﾚｰｱｳﾄ－3
";
CM_ SG_ 552 RDR228_1_7_CSTM_GLO_2 "ｶｽﾀﾏｲｽﾞ表示ｸﾞﾚｰｱｳﾄ－2
";
CM_ SG_ 552 RDR228_0_0_CHECK_SUM "ﾁｪｯｸｻﾑ
";
CM_ SG_ 967 EYE3C7_7_3_WARN_ESCALATION_REQ "警報エスカレーション連動
";
CM_ SG_ 967 EYE3C7_7_6_AEB_MSB_LINK "AEB連動信号
";
CM_ SG_ 967 EYE3C7_4_0_LKS_DMS_COOPERATION "LKS_DMS連携有無
";
CM_ SG_ 967 EYE3C7_4_1_LKS_ACTIVE "LKSアクティブ状態
";
CM_ SG_ 967 EYE3C7_2_0_ALC_CONTROL "ALC制御状態
";
CM_ SG_ 967 EYE3C7_2_1_WINKER_OFF_REQ "ウィンカー消灯要求
";
CM_ SG_ 967 EYE3C7_2_2_HORN_HAZARD_ON_REQ "ホーンハザード駆動要求
";
CM_ SG_ 967 EYE3C7_2_4_DR_UNLOCK_REQ "ドアアンロック要求
";
CM_ SG_ 967 EYE3C7_2_5_WINKER_ON_REQ "ウィンカー点灯要求
";
CM_ SG_ 967 EYE3C7_2_7_MRM_ACTIVE "MRMアクティブ状態
";
CM_ SG_ 967 EYE3C7_1_0_MSG_COUNTER "ﾒｯｾｰｼﾞｶｳﾝﾀ
";
CM_ SG_ 967 EYE3C7_0_0_CHECK_SUM "ﾁｪｯｸｻﾑ
";
CM_ SG_ 964 EYE3C4_7_0_PCR_FAIL_OFF_IND "プリクラ故障/OFF灯指示
";
CM_ SG_ 964 EYE3C4_7_2_AES_FAIL_OFF_IND "AES故障/OFF灯指示
";
CM_ SG_ 964 EYE3C4_7_4_LDP_FAIL_OFF_IND "LDP故障/OFF灯指示
";
CM_ SG_ 964 EYE3C4_7_6_ELK_FAIL_OFF_IND "ELK故障/OFF灯指示
";
CM_ SG_ 964 EYE3C4_6_0_MCAM_SYS_FAIL_HALT "単眼故障状態通知(HALT/FAIL)
";
CM_ SG_ 964 EYE3C4_6_2_MCAM_FUNC_INFO "単眼機能有無フラグ
";
CM_ SG_ 964 EYE3C4_6_3_EYE_DRV_ACTION_REQ "アイサイトドライバアクション要求
";
CM_ SG_ 964 EYE3C4_6_6_LDW_SND_OFF_FAIL_IND "LDW音OFF灯/SW故障警告表示
";
CM_ SG_ 964 EYE3C4_5_0_EAM_GREEN "EAM点灯指示　緑
";
CM_ SG_ 964 EYE3C4_5_2_EAM_BLUE "EAM点灯指示　青
";
CM_ SG_ 964 EYE3C4_5_4_EAM_GREEN_2 "EAM点灯指示_緑2
";
CM_ SG_ 964 EYE3C4_5_6_FCW_SND_OFF_FAIL_IND "FCW音OFF灯/SW故障警告表示
";
CM_ SG_ 964 EYE3C4_4_0_EAM_YELLOW "EAM点灯指示　黄
";
CM_ SG_ 964 EYE3C4_4_4_EAM_RED "EAM点灯指示　赤
";
CM_ SG_ 964 EYE3C4_3_0_CODE_NO_BUZZER "警報コード（表示のみ）
";
CM_ SG_ 964 EYE3C4_2_0_CODE_WARN "警報コード（音有）
";
CM_ SG_ 964 EYE3C4_1_0_MSG_COUNTER "ﾒｯｾｰｼﾞｶｳﾝﾀ
";
CM_ SG_ 964 EYE3C4_1_5_SNR_DRV_ACTION_REQ "ソナードライバアクション要求
";
CM_ SG_ 964 EYE3C4_0_0_CHECK_SUM "ﾁｪｯｸｻﾑ
";
CM_ SG_ 554 EYE22A_5_0_RANGE_RIGHTMOST "検出範囲最右端
";
CM_ SG_ 554 EYE22A_3_0_RANGE_LEFTMOST "検出範囲最左端
";
CM_ SG_ 554 EYE22A_2_0_PERMIT_ADB "ADB許可ﾌﾗｸﾞ
";
CM_ SG_ 554 EYE22A_2_1_HBA_MODE "HBA許可ﾌﾗｸﾞ
";
CM_ SG_ 554 EYE22A_2_2_PROCEEDING "先行車有無ﾌﾗｸﾞ
";
CM_ SG_ 554 EYE22A_2_3_ONCOMING "対向車有無ﾌﾗｸﾞ
";
CM_ SG_ 554 EYE22A_2_4_OBJ_LEFTMOST "最左端対象種別
";
CM_ SG_ 554 EYE22A_2_5_OBJ_RIGHTMOST "最右端対象種別
";
CM_ SG_ 554 EYE22A_2_6_SENSITIVITY_SETTING "感度調整ﾌﾗｸﾞ
";
CM_ SG_ 554 EYE22A_2_7_AHL_DATAFAIL_FLG "AHL通信データ異常フラグ
";
CM_ SG_ 554 EYE22A_1_0_MSG_COUNTER "ﾒｯｾｰｼﾞｶｳﾝﾀ
";
CM_ SG_ 554 EYE22A_1_4_FAIL "ｱｲｻｲﾄﾌｪｰﾙ
";
CM_ SG_ 554 EYE22A_1_5_INIT_END "ｱｲｻｲﾄｶﾒﾗ初期化完了ﾌﾗｸﾞ
";
CM_ SG_ 554 EYE22A_1_6_HALT "ｱｲｻｲﾄHALT
";
CM_ SG_ 554 EYE22A_1_7_EYEVISION_DIRT_FLG "アイサイト汚れ状態フラグ
";
CM_ SG_ 554 EYE22A_0_0_CHECK_SUM "ﾁｪｯｸｻﾑ
";
CM_ SG_ 916 ADAS394_2_2_STRGECU_FAIL "ステアリングヒータ 内部素子異常
";
CM_ SG_ 916 ADAS394_2_1_STRGHTR_OPEN_FAIL "ステアリングヒータ サーミスタ断線
";
CM_ SG_ 916 ADAS394_2_0_STRGHTR_SHORT_FAIL "ステアリングヒータ サーミスタ短絡
";
CM_ SG_ 916 ADAS394_1_7_COMM_STRGECU "統合ECU⇔STRG ECU通信状態
";
CM_ SG_ 916 ADAS394_1_4_STRGHTR_STATE "ステアリングヒータ作動状態
";
CM_ SG_ 916 ADAS394_1_0_MSG_COUNTER "ﾒｯｾｰｼﾞｶｳﾝﾀ
";
CM_ SG_ 916 ADAS394_0_0_CHECK_SUM "ﾁｪｯｸｻﾑ
";
CM_ SG_ 857 THM359_5_1_HVBOUTLTEMPREL "電池出口水温センサ信頼性情報
";
CM_ SG_ 857 THM359_4_0_HVBOUTLTEMP "電池出口水温センサ温度
";
CM_ SG_ 857 THM359_3_1_HVBINLTEMPREL "電池入口水温センサ信頼性情報
";
CM_ SG_ 857 THM359_3_3_IJDRMDTRFREQ "注排水移行要求
";
CM_ SG_ 857 THM359_2_0_HVBINLTEMP "電池入口水温センサ温度
";
CM_ SG_ 857 THM359_1_0_MSG_COUNTER "メッセージカウンタ
";
CM_ SG_ 857 THM359_0_0_CHECK_SUM "チェックサム
";
CM_ SG_ 855 THM357_7_0_ACNINVTEMP "エアコンインバータ温度信号
";
CM_ SG_ 855 THM357_6_0_ACNINVINI "エアコンインバータイニシャルフラグ
";
CM_ SG_ 855 THM357_6_1_THMADJRSVCCSSTT "予約空調ステータス
";
CM_ SG_ 855 THM357_5_0_NVLMT "充電中の電池冷却能力向上許可
";
CM_ SG_ 855 THM357_5_1_ACNHVDDRVADM "エアコン高圧デバイス駆動許可
";
CM_ SG_ 855 THM357_5_3_SOAKTIM "ソーク時間
";
CM_ SG_ 855 THM357_4_0_INVCPUABN "エアコンインバータCPUエラーフラグ
";
CM_ SG_ 855 THM357_4_2_ACNINIEXEADM "エアコンイニシャライズ実施許可
";
CM_ SG_ 855 THM357_4_3_ACNINHSIG "空調禁止信号
";
CM_ SG_ 855 THM357_4_4_DRVBATCLG "駆動用電池冷却フラグ
";
CM_ SG_ 855 THM357_4_5_DRVBATWRM "駆動用電池昇温フラグ
";
CM_ SG_ 855 THM357_4_6_OILCLCTADM "オイル回収可否
";
CM_ SG_ 855 THM357_2_0_ACNINPWR "ｴｱｺﾝ入力電力
";
CM_ SG_ 855 THM357_0_0_MSG_COUNTER "メッセージカウンタ
";
CM_ SG_ 855 THM357_0_0_CHECK_SUM "チェックサム
";
CM_ SG_ 854 THM356_7_0_INVTEMPSNSABN "温度センサ異常
";
CM_ SG_ 854 THM356_7_1_STBSTT "STB状態(STBS)
";
CM_ SG_ 854 THM356_7_2_INVINTERR "Internal Error
";
CM_ SG_ 854 THM356_7_4_SELFINVCHK "ｾﾙﾌﾁｪｯｸ
";
CM_ SG_ 854 THM356_7_5_INVINTPWRABN "A/Cｲﾝﾊﾞｰﾀ内部電源異常
";
CM_ SG_ 854 THM356_6_0_INVCURSNSABN "電流センサ異常
";
CM_ SG_ 854 THM356_6_1_ACNMOTCTRLABN "モータ制御異常
";
CM_ SG_ 854 THM356_6_3_ACNCMNSTT_INV "ｴｱｺﾝｲﾝﾊﾞｰﾀ⇔統合ECU通信状態信号(インバータ検出)
";
CM_ SG_ 854 THM356_6_4_CMPSTT "コンプレッサ状態
";
CM_ SG_ 854 THM356_6_7_RESLOTEMPABN "ｻｰﾐｽﾀ低温異常
";
CM_ SG_ 854 THM356_5_2_FRCDAIRCYCLREQ "強制内気要求
";
CM_ SG_ 854 THM356_5_3_ACNCMNSTT_ICU "ｴｱｺﾝｲﾝﾊﾞｰﾀ⇔統合ECU通信状態信号(統合検出)
";
CM_ SG_ 854 THM356_5_4_INVMAINVLTDIAG "A/Cｲﾝﾊﾞｰﾀ主電源電圧ﾀﾞｲｱｸﾞ信号
";
CM_ SG_ 854 THM356_5_6_INVOVRHEAT "過熱系フラグ
";
CM_ SG_ 854 THM356_4_0_ACNSYSADMPWR "エアコンシステム使用許可電力
";
CM_ SG_ 854 THM356_2_0_ACNMOTSPD "A/C用ﾓｰﾀ回転数
";
CM_ SG_ 854 THM356_1_0_MSG_COUNTER "メッセージカウンタ
";
CM_ SG_ 854 THM356_0_0_CHECK_SUM "チェックサム
";
CM_ SG_ 853 THM355_6_0_LTCRFNWASTCALRLV "LTラジ放熱レベル
";
CM_ SG_ 853 THM355_6_3_ACNOVRLDSTT "過負荷警報
";
CM_ SG_ 853 THM355_6_5_STRTLMTSTT "起動制限状態信号
";
CM_ SG_ 853 THM355_6_6_DLYSTRTSTT "スロースタート状態信号
";
CM_ SG_ 853 THM355_5_7_HVHLKCHKOPEREQ "HVH漏電部位特定駆動要求
";
CM_ SG_ 853 THM355_4_0_HWPINSTDUTY "HT W/P指令duty
";
CM_ SG_ 853 THM355_3_2_HVHSTBOP "HVH STB線断線フラグ
";
CM_ SG_ 853 THM355_3_4_HVHSTBSTT "HVH STB状態フラグ
";
CM_ SG_ 853 THM355_3_6_HVHOPEHLD "水加熱ヒータ駆動保持制御状態
";
CM_ SG_ 853 THM355_2_0_HTFWVINSTDEG "HT4方弁駆動指示開度
";
CM_ SG_ 853 THM355_1_0_MSG_COUNTER "メッセージカウンタ
";
CM_ SG_ 853 THM355_0_0_CHECK_SUM "チェックサム
";
CM_ SG_ 852 THM354_7_0_HVHCLTPHI "HVH冷却水温度高温
";
CM_ SG_ 852 THM354_7_5_HVHOVHTSTT "HVHオーバーヒート検出
";
CM_ SG_ 852 THM354_7_7_HVHINTCMNABN "HVH内部通信エラー
";
CM_ SG_ 852 THM354_6_0_HVHVLT "HVH12Ｖ側電圧値
";
CM_ SG_ 852 THM354_5_0_HVHACTCNSPCUR "HVH実消費電流
";
CM_ SG_ 852 THM354_4_0_HVHINLCLTP "HVH入口水温
";
CM_ SG_ 852 THM354_3_0_HVHOUTLCLTP "HVH出口水温
";
CM_ SG_ 852 THM354_2_0_HVHIGBTABN "HVH　IGBT異常検出
";
CM_ SG_ 852 THM354_2_1_HVHSTBSTT "HVH STB状態フラグ
";
CM_ SG_ 852 THM354_2_3_HVHMEMABN "HVHメモリーエラー
";
CM_ SG_ 852 THM354_2_4_HVHSERVREQ "HVHサービス要求
";
CM_ SG_ 852 THM354_2_5_HVHSTTFBK "HVH状態フィードバック
";
CM_ SG_ 852 THM354_1_0_MSG_COUNTER "メッセージカウンタ
";
CM_ SG_ 852 THM354_1_4_HVHINLCLTPABN "HVH入口水温センサ異常
";
CM_ SG_ 852 THM354_1_5_HVHOUTLCLTPABN "HVH出口水温センサ異常
";
CM_ SG_ 852 THM354_1_6_HVHOVHTABN "HVHオーバーヒート検出センサ異常
";
CM_ SG_ 852 THM354_1_7_HVHLINABN "HVH LIN通信エラー
";
CM_ SG_ 852 THM354_0_0_CHECK_SUM "チェックサム
";
CM_ SG_ 851 THM353_7_5_LTCHTGLV "LT回路昇温レベル
";
CM_ SG_ 851 THM353_6_2_IMXANSCALR "水水IMX回答熱量
";
CM_ SG_ 851 THM353_5_1_LTCHTGTGTCLTP "LT回路昇温目標水温
";
CM_ SG_ 851 THM353_4_0_LTCCLGTGTCLTP "LT回路冷却目標水温
";
CM_ SG_ 851 THM353_3_3_LTCCLGLV "LT回路冷却レベル
";
CM_ SG_ 851 THM353_3_6_DEFRANS "除霜要求に対する回答
";
CM_ SG_ 851 THM353_3_7_CDVINIREQ "10方弁イニシャライズ要求
";
CM_ SG_ 851 THM353_2_0_CHILANSCALR "チラー回答吸熱量
";
CM_ SG_ 851 THM353_1_0_MSG_COUNTER "メッセージカウンタ
";
CM_ SG_ 851 THM353_1_4_CHILCLTPCHNGSTT "チラー水温急変状態
";
CM_ SG_ 851 THM353_0_0_CHECK_SUM "チェックサム
";
CM_ SG_ 850 THM352_7_2_HVHOVHTSTT "HVHオーバーヒート検出
";
CM_ SG_ 850 THM352_7_4_HVHINLCLTPABN "HVH入口水温センサ異常
";
CM_ SG_ 850 THM352_7_5_HVHOUTLCLTPABN "HVH出口水温センサ異常
";
CM_ SG_ 850 THM352_7_6_HVHOVHTABN "HVHオーバーヒート検出センサ異常
";
CM_ SG_ 850 THM352_7_7_HVHLINABN "HVH LIN通信エラー
";
CM_ SG_ 850 THM352_6_0_CDVINDDEG "LT10方弁指示開度
";
CM_ SG_ 850 THM352_5_3_LTCCHNGREQ "LT回路切替要求（空調回路切替判定用）
";
CM_ SG_ 850 THM352_4_6_LTCSTT "LT回路状態（空調回路切替判定用）
";
CM_ SG_ 850 THM352_3_0_BWPINSTDUTY "バッテリーW/P指令duty
";
CM_ SG_ 850 THM352_2_0_RFRCCHNGREQ "冷媒回路切替要求
";
CM_ SG_ 850 THM352_2_4_CHILCLTPCHNGSTT "チラー水温変更有無
";
CM_ SG_ 850 THM352_1_0_MSG_COUNTER "メッセージカウンタ
";
CM_ SG_ 850 THM352_1_4_HVHPRTRUN "HVH保護作動中
";
CM_ SG_ 850 THM352_1_5_BWPSTRTFLG "バッテリー用W/P起動停止フラグ
";
CM_ SG_ 850 THM352_1_6_EXSTTEMPABN "排気温度上昇異常
";
CM_ SG_ 850 THM352_0_0_CHECK_SUM "チェックサム
";
CM_ SG_ 1537 BEV601_2_0_IMBSTS "イモビ状態
";
CM_ SG_ 1537 BEV601_2_1_RDYNGSTS "ReadyON不可
";
CM_ SG_ 1537 BEV601_1_0_MSG_COUNTER "ﾒｯｾｰｼﾞｶｳﾝﾀ
";
CM_ SG_ 1537 BEV601_1_4_CDEVANS "衝突検知信号(EV用)アンサーバック
";
CM_ SG_ 1537 BEV601_0_0_CHECK_SUM "ﾁｪｯｸｻﾑ
";
CM_ SG_ 267 BEV10B_6_7_SPEC8 "特殊分母8
";
CM_ SG_ 267 BEV10B_6_6_SPEC7 "特殊分母7
";
CM_ SG_ 267 BEV10B_6_5_SPEC6 "特殊分母6
";
CM_ SG_ 267 BEV10B_6_4_SPEC5 "特殊分母5
";
CM_ SG_ 267 BEV10B_6_3_SPEC4 "特殊分母4
";
CM_ SG_ 267 BEV10B_6_2_SPEC3 "特殊分母3
";
CM_ SG_ 267 BEV10B_6_1_SPEC2 "特殊分母2
";
CM_ SG_ 267 BEV10B_6_0_SPEC1 "特殊分母1
";
CM_ SG_ 267 BEV10B_5_2_DENO "一般分母
";
CM_ SG_ 267 BEV10B_5_1_PROHIBIT_INC "分子分母インクリメント禁止フラグ
";
CM_ SG_ 267 BEV10B_5_0_PERMIT_INC "一般分母インクリメント許可フラグ
";
CM_ SG_ 267 BEV10B_4_0_DCCNT "ドライビングサイクルカウンタ
";
CM_ SG_ 267 BEV10B_3_2_OBDRDY "OBD Ready状態
";
CM_ SG_ 267 BEV10B_3_0_DRVRDY "運転可能表示状態
";
CM_ SG_ 267 BEV10B_1_0_MSG_COUNTER "ﾒｯｾｰｼﾞｶｳﾝﾀ
";
CM_ SG_ 267 BEV10B_0_0_CHECK_SUM "ﾁｪｯｸｻﾑ
";
CM_ SG_ 116 BEV074_7_0_LVPWRDWN "12V電力抑制信号
";
CM_ SG_ 116 BEV074_7_6_CHRCONSTA "充電コネクタ接続状態
";
CM_ SG_ 116 BEV074_7_7_VEHICLE_IGN "車両イグニッション情報
";
CM_ SG_ 116 BEV074_6_0_EV_CAU "EVコーション点灯要求
";
CM_ SG_ 116 BEV074_6_2_BEV_OBD_CAU "BEV_OBD警告灯点灯要求
";
CM_ SG_ 116 BEV074_6_5_SIDRIVE_DISP "SIドライブモード表示情報
";
CM_ SG_ 116 BEV074_5_0_ACCHG_STATE "AC充電状態
";
CM_ SG_ 116 BEV074_5_1_DCCHG_STATE "DC充電状態
";
CM_ SG_ 116 BEV074_5_2_RANGE_DG "シフト故障状態
";
CM_ SG_ 116 BEV074_5_3_ACCP_DG "アクセル故障状態
";
CM_ SG_ 116 BEV074_5_4_REZ_SPD_BK "レゾルバ車速バックアップ状態
";
CM_ SG_ 116 BEV074_5_6_OBDRDY "OBD Ready状態
";
CM_ SG_ 116 BEV074_5_7_FHVB "高電圧バッテリ異常
";
CM_ SG_ 116 BEV074_3_0_RANGE_POS "現在レンジ位置情報
";
CM_ SG_ 116 BEV074_3_3_DRVRDY "運転可能表示状態
";
CM_ SG_ 116 BEV074_3_5_HVSYSTS "高電圧システムステータス
";
CM_ SG_ 116 BEV074_3_7_REZ_SPD_GL "レゾルバ車速_GL
";
CM_ SG_ 116 BEV074_2_0_ACCP_USR "アクセル開度(ユーザー)
";
CM_ SG_ 116 BEV074_1_0_MSG_COUNTER "ﾒｯｾｰｼﾞｶｳﾝﾀ
";
CM_ SG_ 116 BEV074_1_4_RANGE_DG2 "シフト故障状態2
";
CM_ SG_ 116 BEV074_1_5_REZ_SPD_BK "レゾルバ車速バックアップ状態
";
CM_ SG_ 116 BEV074_0_0_CHECK_SUM "ﾁｪｯｸｻﾑ
";
CM_ SG_ 2564481103 PSM18DAE04F_DIAG_DATA "ﾃﾞｰﾀ
";
CM_ SG_ 2564444128 DNT18DA4FE0_DIAG_DATA "ﾃﾞｰﾀ
";
CM_ SG_ 2564481205 MEP18DAE0B5_DIAG_DATA "ﾃﾞｰﾀ
";
CM_ SG_ 2564470240 DNT18DAB5E0_DIAG_DATA "ﾃﾞｰﾀ
";
CM_ SG_ 2564481204 MED18DAE0B4_DIAG_DATA "ﾃﾞｰﾀ
";
CM_ SG_ 2564469984 DNT18DAB4E0_DIAG_DATA "ﾃﾞｰﾀ
";
CM_ SG_ 2564481150 PRG18DAE07E_DIAG_DATA "ﾃﾞｰﾀ
";
CM_ SG_ 2564456160 DNT18DA7EE0_DIAG_DATA "ﾃﾞｰﾀ
";
CM_ SG_ 1865 DAM749_7_0_DIAG_DATA "ﾃﾞｰﾀ
";
CM_ SG_ 1865 DAM749_2_0_DIAG_N_PCI_OR_DATA "N_PCI　 or 　ﾃﾞｰﾀ
";
CM_ SG_ 1865 DAM749_1_0_DIAG_N_PCI_OR_DATA "N_PCI　 or 　ﾃﾞｰﾀ
";
CM_ SG_ 1865 DAM749_0_0_DIAG_N_PCI "N_PCI
";
CM_ SG_ 1857 DNT741_7_0_DIAG_DATA "ﾃﾞｰﾀ
";
CM_ SG_ 1857 DNT741_2_0_DIAG_N_PCI_OR_DATA "N_PCI　 or 　ﾃﾞｰﾀ
";
CM_ SG_ 1857 DNT741_1_0_DIAG_N_PCI_OR_DATA "N_PCI　 or 　ﾃﾞｰﾀ
";
CM_ SG_ 1857 DNT741_0_0_DIAG_N_PCI "N_PCI
";
CM_ SG_ 1851 EAM73B_7_0_DIAG_DATA "ﾃﾞｰﾀ
";
CM_ SG_ 1851 EAM73B_2_0_DIAG_N_PCI_OR_DATA "N_PCI　 or 　ﾃﾞｰﾀ
";
CM_ SG_ 1851 EAM73B_1_0_DIAG_N_PCI_OR_DATA "N_PCI　 or 　ﾃﾞｰﾀ
";
CM_ SG_ 1851 EAM73B_0_0_DIAG_N_PCI "N_PCI
";
CM_ SG_ 1843 DNT733_7_0_DIAG_DATA "ﾃﾞｰﾀ
";
CM_ SG_ 1843 DNT733_2_0_DIAG_N_PCI_OR_DATA "N_PCI　 or 　ﾃﾞｰﾀ
";
CM_ SG_ 1843 DNT733_1_0_DIAG_N_PCI_OR_DATA "N_PCI　 or 　ﾃﾞｰﾀ
";
CM_ SG_ 1843 DNT733_0_0_DIAG_N_PCI "N_PCI
";
CM_ SG_ 2564481214 RKE18DAE0BE_DIAG_DATA "ﾃﾞｰﾀ
";
CM_ SG_ 2564472544 DNT18DABEE0_DIAG_DATA "ﾃﾞｰﾀ
";
CM_ SG_ 2564481090 AHL18DAE042_DIAG_DATA "ﾃﾞｰﾀ
";
CM_ SG_ 2564440800 DNT18DA42E0_DIAG_DATA "ﾃﾞｰﾀ
";
CM_ SG_ 2564468769 BIU18DAB021_DIAG_DATA "ﾃﾞｰﾀ
";
CM_ SG_ 2564432304 AVN18DA21B0_DIAG_DATA "ﾃﾞｰﾀ
";
CM_ SG_ 2564481142 TPM18DAE076_DIAG_DATA "ﾃﾞｰﾀ
";
CM_ SG_ 2564454112 DNT18DA76E0_DIAG_DATA "ﾃﾞｰﾀ
";
CM_ SG_ 2564481057 BIU18DAE021_DIAG_DATA "ﾃﾞｰﾀ
";
CM_ SG_ 2564432352 DNT18DA21E0_DIAG_DATA "ﾃﾞｰﾀ
";
CM_ SG_ 1993 PMN7C9_7_0_DIAG_DATA "ﾃﾞｰﾀ
";
CM_ SG_ 1993 PMN7C9_2_0_DIAG_N_PCI_OR_DATA "N_PCI　 or 　ﾃﾞｰﾀ
";
CM_ SG_ 1993 PMN7C9_1_0_DIAG_N_PCI_OR_DATA "N_PCI　 or 　ﾃﾞｰﾀ
";
CM_ SG_ 1993 PMN7C9_0_0_DIAG_N_PCI "N_PCI
";
CM_ SG_ 1985 DNT7C1_7_0_DIAG_DATA "ﾃﾞｰﾀ
";
CM_ SG_ 1985 DNT7C1_2_0_DIAG_N_PCI_OR_DATA "N_PCI　 or 　ﾃﾞｰﾀ
";
CM_ SG_ 1985 DNT7C1_1_0_DIAG_N_PCI_OR_DATA "N_PCI　 or 　ﾃﾞｰﾀ
";
CM_ SG_ 1985 DNT7C1_0_0_DIAG_N_PCI "N_PCI
";
CM_ SG_ 1980 SMT7BC_7_0_DIAG_DATA "ﾃﾞｰﾀ
";
CM_ SG_ 1980 SMT7BC_2_0_DIAG_N_PCI_OR_DATA "N_PCI　 or 　ﾃﾞｰﾀ
";
CM_ SG_ 1980 SMT7BC_1_0_DIAG_N_PCI_OR_DATA "N_PCI　 or 　ﾃﾞｰﾀ
";
CM_ SG_ 1980 SMT7BC_0_0_DIAG_N_PCI "N_PCI
";
CM_ SG_ 1972 DNT7B4_7_0_DIAG_DATA "ﾃﾞｰﾀ
";
CM_ SG_ 1972 DNT7B4_2_0_DIAG_N_PCI_OR_DATA "N_PCI　 or 　ﾃﾞｰﾀ
";
CM_ SG_ 1972 DNT7B4_1_0_DIAG_N_PCI_OR_DATA "N_PCI　 or 　ﾃﾞｰﾀ
";
CM_ SG_ 1972 DNT7B4_0_0_DIAG_N_PCI "N_PCI
";
CM_ SG_ 2564502513 DNT18DB33F1_DIAG_DATA "ﾃﾞｰﾀ
";
CM_ SG_ 2564485528 ACN18DAF198_DIAG_DATA "ﾃﾞｰﾀ
";
CM_ SG_ 2564462833 DNT18DA98F1_DIAG_DATA "ﾃﾞｰﾀ
";
CM_ SG_ 2564481176 ACN18DAE098_DIAG_DATA "ﾃﾞｰﾀ
";
CM_ SG_ 2564462816 DNT18DA98E0_DIAG_DATA "ﾃﾞｰﾀ
";
CM_ SG_ 1919 ACN77F_7_0_DIAG_DATA "ﾃﾞｰﾀ
";
CM_ SG_ 1919 ACN77F_2_0_DIAG_N_PCI_OR_DATA "N_PCI　 or 　ﾃﾞｰﾀ
";
CM_ SG_ 1919 ACN77F_1_0_DIAG_N_PCI_OR_DATA "N_PCI　 or 　ﾃﾞｰﾀ
";
CM_ SG_ 1919 ACN77F_0_0_DIAG_N_PCI "N_PCI
";
CM_ SG_ 1911 DNT777_7_0_DIAG_DATA "ﾃﾞｰﾀ
";
CM_ SG_ 1911 DNT777_2_0_DIAG_N_PCI_OR_DATA "N_PCI　 or 　ﾃﾞｰﾀ
";
CM_ SG_ 1911 DNT777_1_0_DIAG_N_PCI_OR_DATA "N_PCI　 or 　ﾃﾞｰﾀ
";
CM_ SG_ 1911 DNT777_0_0_DIAG_N_PCI "N_PCI
";
CM_ SG_ 1996 ACN7CC_7_0_DIAG_DATA "ﾃﾞｰﾀ
";
CM_ SG_ 1996 ACN7CC_2_0_DIAG_N_PCI_OR_DATA "N_PCI　 or 　ﾃﾞｰﾀ
";
CM_ SG_ 1996 ACN7CC_1_0_DIAG_N_PCI_OR_DATA "N_PCI　 or 　ﾃﾞｰﾀ
";
CM_ SG_ 1996 ACN7CC_0_0_DIAG_N_PCI "N_PCI
";
CM_ SG_ 1988 DNT7C4_7_0_DIAG_DATA "ﾃﾞｰﾀ
";
CM_ SG_ 1988 DNT7C4_2_0_DIAG_N_PCI_OR_DATA "N_PCI　 or 　ﾃﾞｰﾀ
";
CM_ SG_ 1988 DNT7C4_1_0_DIAG_N_PCI_OR_DATA "N_PCI　 or 　ﾃﾞｰﾀ
";
CM_ SG_ 1988 DNT7C4_0_0_DIAG_N_PCI "N_PCI
";
CM_ SG_ 2564550625 CECU18DBEFE1_DIAG_DATA "ﾃﾞｰﾀ
";
CM_ SG_ 2564550624 DNT18DBEFE0_DIAG_DATA "ﾃﾞｰﾀ
";
CM_ SG_ 1832 DNT728_7_0_DIAG_DATA "ﾃﾞｰﾀ
";
CM_ SG_ 1832 DNT728_2_0_DIAG_N_PCI_OR_DATA "N_PCI　 or 　ﾃﾞｰﾀ
";
CM_ SG_ 1832 DNT728_1_0_DIAG_N_PCI_OR_DATA "N_PCI　 or 　ﾃﾞｰﾀ
";
CM_ SG_ 1832 DNT728_0_0_DIAG_N_PCI "N_PCI
";
CM_ SG_ 1880 RBB758_7_0_DIAG_DATA "ﾃﾞｰﾀ
";
CM_ SG_ 1880 RBB758_3_0_DIAG_N_PCI_OR_DATA "N_PCI　 or 　ﾃﾞｰﾀ
";
CM_ SG_ 1880 RBB758_2_0_DIAG_N_PCI_OR_DATA "N_PCI　 or 　ﾃﾞｰﾀ
";
CM_ SG_ 1880 RBB758_1_0_DIAG_N_PCI "N_PCI
";
CM_ SG_ 1880 RBB758_0_0_DIAG_N_TA "N_TA
";
CM_ SG_ 1872 DNT750_7_0_DIAG_DATA "ﾃﾞｰﾀ
";
CM_ SG_ 1872 DNT750_3_0_DIAG_N_PCI_OR_DATA "N_PCI　 or 　ﾃﾞｰﾀ
";
CM_ SG_ 1872 DNT750_2_0_DIAG_N_PCI_OR_DATA "N_PCI　 or 　ﾃﾞｰﾀ
";
CM_ SG_ 1872 DNT750_1_0_DIAG_N_PCI "N_PCI
";
CM_ SG_ 1872 DNT750_0_0_DIAG_N_TA "N_TA
";
CM_ SG_ 2564481453 EAM18DAE1AD_DIAG_DATA "ﾃﾞｰﾀ
";
CM_ SG_ 2564468193 CECU18DAADE1_DIAG_DATA "ﾃﾞｰﾀ
";
CM_ SG_ 2564481359 PSM18DAE14F_DIAG_DATA "ﾃﾞｰﾀ
";
CM_ SG_ 2564444129 CECU18DA4FE1_DIAG_DATA "ﾃﾞｰﾀ
";
CM_ SG_ 2564481406 PRG18DAE17E_DIAG_DATA "ﾃﾞｰﾀ
";
CM_ SG_ 2564456161 CECU18DA7EE1_DIAG_DATA "ﾃﾞｰﾀ
";
CM_ SG_ 2564481346 AHL18DAE142_DIAG_DATA "ﾃﾞｰﾀ
";
CM_ SG_ 2564440801 CECU18DA42E1_DIAG_DATA "ﾃﾞｰﾀ
";
CM_ SG_ 2564481398 TPM18DAE176_DIAG_DATA "ﾃﾞｰﾀ
";
CM_ SG_ 2564454113 CECU18DA76E1_DIAG_DATA "ﾃﾞｰﾀ
";
CM_ SG_ 2564481313 BIU18DAE121_DIAG_DATA "ﾃﾞｰﾀ
";
CM_ SG_ 2564432353 CECU18DA21E1_DIAG_DATA "ﾃﾞｰﾀ
";
CM_ SG_ 1774 CECU6EE_7_0_DESTINATION_INFO "仕向地情報
";
CM_ SG_ 1774 CECU6EE_7_4_VEHICLE_SERIES "車系情報
";
CM_ SG_ 1774 CECU6EE_6_0_DESTINATION_CODE "仕向地ｺｰﾄﾞ
";
CM_ SG_ 1774 CECU6EE_5_0_EYE_VERSION_INFO "ｱｲｻｲﾄVer情報
";
CM_ SG_ 1774 CECU6EE_5_4_VEHICLE_TYPE "車型情報
";
CM_ SG_ 1774 CECU6EE_5_6_PRODUCTION_BASE "生産拠点
";
CM_ SG_ 1774 CECU6EE_4_2_WHEEL_DRIVE_TYPE "駆動方式
";
CM_ SG_ 1774 CECU6EE_4_3_3RD_SHEAT_EQUIPMENT "3rdｼｰﾄ有無
";
CM_ SG_ 1774 CECU6EE_4_4_FLG_XMODE "Xﾓｰﾄﾞ有無
";
CM_ SG_ 1774 CECU6EE_4_6_ISS_EQUIPMENT "ISS有無
";
CM_ SG_ 1774 CECU6EE_4_7_TIRE_INFO "ﾀｲﾔ情報
";
CM_ SG_ 1774 CECU6EE_1_0_MSG_COUNTER "ﾒｯｾｰｼﾞｶｳﾝﾀ
";
CM_ SG_ 1774 CECU6EE_1_5_BEV_WHEEL_DRIVE_TYPE "駆動方式(BEV)
";
CM_ SG_ 1774 CECU6EE_0_0_CHECK_SUM "ﾁｪｯｸｻﾑ
";
CM_ SG_ 1773 CECU6ED_7_0_VEHICLE_TYPE_DETAIL "車型情報(詳細)
";
CM_ SG_ 1773 CECU6ED_5_0_TRANSMISSION_TYPE "ﾄﾗﾝｽﾐｯｼｮﾝ情報
";
CM_ SG_ 1773 CECU6ED_5_4_HANDLE "ﾊﾝﾄﾞﾙ情報
";
CM_ SG_ 1773 CECU6ED_4_0_VEHICLE_HEIGHT "車高情報
";
CM_ SG_ 1773 CECU6ED_4_4_SEATHEATER_EQUIPMENT "ｼｰﾄﾋｰﾀｰ有無
";
CM_ SG_ 1773 CECU6ED_3_0_YEAR_CHANGE "年改情報
";
CM_ SG_ 1773 CECU6ED_3_4_HEV_INFO "HEV情報
";
CM_ SG_ 1773 CECU6ED_1_0_MSG_COUNTER "ﾒｯｾｰｼﾞｶｳﾝﾀ
";
CM_ SG_ 1773 CECU6ED_0_0_CHECK_SUM "ﾁｪｯｸｻﾑ
";
CM_ SG_ 1772 CECU6EC_6_0_SMT_EQUIPMENT "SMT有無
";
CM_ SG_ 1772 CECU6EC_6_1_DCCD_EQUIPMENT "DCCD有無
";
CM_ SG_ 1772 CECU6EC_6_2_PRG_EQUIPMENT "PRG有無
";
CM_ SG_ 1772 CECU6EC_6_3_DKY_EQUIPMENT "DKY有無
";
CM_ SG_ 1772 CECU6EC_6_4_PSC_EQUIPMENT "PSC有無
";
CM_ SG_ 1772 CECU6EC_5_0_CCU_EQUIPMENT "CCU有無
";
CM_ SG_ 1772 CECU6EC_5_1_EAM_EQUIPMENT "EAM有無
";
CM_ SG_ 1772 CECU6EC_5_2_RCR_L_EQUIPMENT "RCR-L有無
";
CM_ SG_ 1772 CECU6EC_5_3_RCR_R_EQUIPMENT "RCR-R有無
";
CM_ SG_ 1772 CECU6EC_5_4_FCR_L_EQUIPMENT "FCR-L有無
";
CM_ SG_ 1772 CECU6EC_5_5_FCR_R_EQUIPMENT "FCR-R有無
";
CM_ SG_ 1772 CECU6EC_5_6_VSS_EQUIPMENT "VSS有無
";
CM_ SG_ 1772 CECU6EC_5_7_RES_EQUIPMENT "RES有無
";
CM_ SG_ 1772 CECU6EC_4_0_LCT_EQUIPMENT "LCT有無
";
CM_ SG_ 1772 CECU6EC_4_1_DAM_EQUIPMENT "DAM有無
";
CM_ SG_ 1772 CECU6EC_4_2_MVS_EQUIPMENT "MVS有無
";
CM_ SG_ 1772 CECU6EC_4_3_TCU_EQUIPMENT "TCU有無
";
CM_ SG_ 1772 CECU6EC_4_4_TPM_EQUIPMENT "TPM有無
";
CM_ SG_ 1772 CECU6EC_4_5_DCM_EQUIPMENT "DCM有無
";
CM_ SG_ 1772 CECU6EC_4_6_MED_EQUIPMENT "MED有無
";
CM_ SG_ 1772 CECU6EC_4_7_MEP_EQUIPMENT "MEP有無
";
CM_ SG_ 1772 CECU6EC_3_0_DATA_STATE "ﾃﾞｰﾀ状態
";
CM_ SG_ 1772 CECU6EC_3_1_EYE_EQUIPMENT "EYE有無
";
CM_ SG_ 1772 CECU6EC_3_2_HEV_EQUIPMENT "HEV有無
";
CM_ SG_ 1772 CECU6EC_3_3_SNR_EQUIPMENT "SNR有無
";
CM_ SG_ 1772 CECU6EC_3_4_EPB_EQUIPMENT "EPB有無
";
CM_ SG_ 1772 CECU6EC_3_5_DMS_EQUIPMENT "DMS有無
";
CM_ SG_ 1772 CECU6EC_3_6_BST_EQUIPMENT "BST有無
";
CM_ SG_ 1772 CECU6EC_3_7_MCA_EQUIPMENT "MCA有無
";
CM_ SG_ 1772 CECU6EC_1_0_MSG_COUNTER "ﾒｯｾｰｼﾞｶｳﾝﾀ
";
CM_ SG_ 1772 CECU6EC_0_0_CHECK_SUM "ﾁｪｯｸｻﾑ
";
CM_ SG_ 1735 CECU6C7_5_0_BLOWERFAN_SETTING "RCC 風量設定
";
CM_ SG_ 1735 CECU6C7_5_3_STEERING_HTR_AUTO "ステアリングヒータAUTO
";
CM_ SG_ 1735 CECU6C7_5_4_DR_SEAT_HTR_AUTO "シートヒータAUTO D席
";
CM_ SG_ 1735 CECU6C7_5_5_PA_SEAT_HTR_AUTO "シートヒータAUTO P席
";
CM_ SG_ 1735 CECU6C7_4_0_Dr_TEMP_SETTING "RCC 設定温度
";
CM_ SG_ 1735 CECU6C7_4_6_FT_ACN_SETTING "RCC FtエアコンON/OFF設定
";
CM_ SG_ 1735 CECU6C7_4_7_RCC_RDEF_SETTING "RCC リアデフォッガ設定
";
CM_ SG_ 1735 CECU6C7_3_0_VENT_SETTING "RCC エアコン吹き出し口設定
";
CM_ SG_ 1735 CECU6C7_3_4_CIRCULAION_SETTING "RCC 内外気設定
";
CM_ SG_ 1735 CECU6C7_3_6_AUTO3_MODE "RCC AUTO3モード
";
CM_ SG_ 1735 CECU6C7_2_0_DR_H_VENTI_SETTING "RCC D席ヒータ・ベンチレーション設定
";
CM_ SG_ 1735 CECU6C7_2_3_PA_H_VENTI_SETTING "RCC P席ヒータ・ベンチレーション設定
";
CM_ SG_ 1735 CECU6C7_2_6_STRG_H_SETTING "RCC ステアリングヒータ設定
";
CM_ SG_ 1735 CECU6C7_1_0_MSG_COUNTER "ﾒｯｾｰｼﾞｶｳﾝﾀ
";
CM_ SG_ 1735 CECU6C7_1_4_RCC_SETTING_REQ "空調設定要求フラグ
";
CM_ SG_ 1735 CECU6C7_0_0_CHECK_SUM "ﾁｪｯｸｻﾑ
";
CM_ SG_ 996 CECU3E4_7_0_SSM_COMM_INFO "SSM通信情報
";
CM_ SG_ 996 CECU3E4_6_0_CHARGE_LEVEL_ENG_RUN "エンジンRUN中充電レベル
";
CM_ SG_ 996 CECU3E4_6_4_CHARGE_LEVEL_IGN_ON "IG-ONエンスト中充電レベル
";
CM_ SG_ 996 CECU3E4_5_0_GENERATOR_OVER_FLG "発電機過大ﾌﾗｸﾞ
";
CM_ SG_ 996 CECU3E4_5_3_DIAG_COM_REQ "ﾃﾚﾏ診断通信要求
";
CM_ SG_ 996 CECU3E4_5_4_HEADS_UP_FLG "注意喚起ﾌﾗｸﾞ
";
CM_ SG_ 996 CECU3E4_3_0_WASH_CAR_MODE_STS "洗車モード状態
";
CM_ SG_ 996 CECU3E4_2_0_POW_ON_FIX_MODE_STS "電源ON固定モード状態
";
CM_ SG_ 996 CECU3E4_2_3_PET_MODE_STS "ペットモード状態
";
CM_ SG_ 996 CECU3E4_2_6_SHUT_DOWN_MODE_STS "シャットダウンモード遷移可否状態
";
CM_ SG_ 996 CECU3E4_2_7_OCCUPATION_CSTM "乗員検知設定値
";
CM_ SG_ 996 CECU3E4_1_0_MSG_COUNTER "ﾒｯｾｰｼﾞｶｳﾝﾀ
";
CM_ SG_ 996 CECU3E4_0_0_CHECK_SUM "ﾁｪｯｸｻﾑ
";
CM_ SG_ 1280 CGW500_1_4_ActiveWakeUpBit "Active Wakeup ﾌﾗｸﾞ
";
CM_ SG_ 1280 CGW500_0_0_SourceNodeID "送信元ID
";
CM_ SG_ 1633 CECU661_7_0_PRESENT_TIME_SEC "現在時刻(秒)
";
CM_ SG_ 1633 CECU661_6_0_PRESENT_TIME_MIN "現在時刻(分)
";
CM_ SG_ 1633 CECU661_5_0_PRESENT_TIME_HOUR "現在時刻(時)
";
CM_ SG_ 1633 CECU661_4_0_PRESENT_DAY "現在年月日(日)
";
CM_ SG_ 1633 CECU661_3_0_PRESENT_MONTH "現在年月日(月)
";
CM_ SG_ 1633 CECU661_2_0_PRESENT_YEAR "現在年月日(年)
";
CM_ SG_ 1632 CGW660_7_0_COUNT_TIME "時間ｶｳﾝﾀ
";
CM_ SG_ 1632 CGW660_3_0_COUNT_TRIP "Tripｶｳﾝﾀ
";
CM_ SG_ 1632 CGW660_1_0_SUB_ID "ｻﾌﾞID
";
CM_ SG_ 1744 CECU6D0_4_0_OTA_ABORT "OTA中止
";
CM_ SG_ 1744 CECU6D0_4_1_OTA_SUSPEND "OTA中断
";
CM_ SG_ 1744 CECU6D0_4_2_OTA_SEQUENCE "OTA実行シーケンス
";
CM_ SG_ 1744 CECU6D0_1_0_MSG_COUNTER "ﾒｯｾｰｼﾞｶｳﾝﾀ
";
CM_ SG_ 1744 CECU6D0_1_4_OTA_STATUS_UPDATE "OTAステータス アップデート実行中
";
CM_ SG_ 1744 CECU6D0_0_0_CHECK_SUM "ﾁｪｯｸｻﾑ
";
CM_ SG_ 1743 DCM6CF_6_6_AACN_FLG "AACNフラグ
";
CM_ SG_ 1743 DCM6CF_5_0_EMERGENCY_CALL_ON_OFF "緊急通報ON/OFF
";
CM_ SG_ 1743 DCM6CF_4_2_STR_HEATER_ON_OFF "ｽﾃｱﾘﾝｸﾞﾋｰﾀｰ ON/OFF
";
CM_ SG_ 1743 DCM6CF_3_0_RES_CONTRACT_INFO "ﾘﾓｽﾀ契約情報
";
CM_ SG_ 1743 DCM6CF_3_1_REQ_ST_ON "Request ST ON
";
CM_ SG_ 1743 DCM6CF_3_3_ON_SIGN "E/G start signal
";
CM_ SG_ 1743 DCM6CF_3_5_REQ_PARKLIGHT_HORN "Request park light ＆Horn
";
CM_ SG_ 1743 DCM6CF_2_1_DCM_FAILURE_STATUS "DCM故障ｽﾃｰﾀｽ
";
CM_ SG_ 1743 DCM6CF_2_2_REQ_WINDOW_STATUS "窓&ｻﾝﾙｰﾌ開閉状態要求
";
CM_ SG_ 1743 DCM6CF_1_0_MSG_COUNTER "ﾒｯｾｰｼﾞｶｳﾝﾀ
";
CM_ SG_ 1743 DCM6CF_1_6_DKY_PROV_STS "DKCU向けDKY契約状態通知
";
CM_ SG_ 1743 DCM6CF_1_7_PNC_PROV_STS "EVCC向けPnC契約状態通知
";
CM_ SG_ 1743 DCM6CF_0_0_CHECK_SUM "ﾁｪｯｸｻﾑ
";
CM_ SG_ 1630 DCM65E_2_0_DATA2 "Immobilizer Data1
";
CM_ SG_ 1630 DCM65E_1_0_MSG_COUNTER "ﾒｯｾｰｼﾞｶｳﾝﾀ
";
CM_ SG_ 1630 DCM65E_1_4_DATA1 "Immobilizer Mode
";
CM_ SG_ 1630 DCM65E_0_0_CHECK_SUM "ﾁｪｯｸｻﾑ
";
CM_ SG_ 1749 CECU6D5_6_0_CSTM_FMHD "ウェルカムランプ(降車)
";
CM_ SG_ 1749 CECU6D5_5_0_CSTM_WRH "ワイパ連動オートライト機能ON/OFF設定
";
CM_ SG_ 1749 CECU6D5_5_1_CSTM_LMHD "ウェルカムランプ(乗車)
";
CM_ SG_ 1749 CECU6D5_5_3 "北米ウェルカムランプ(リービング)（カスタマイズ）
";
CM_ SG_ 1749 CECU6D5_5_5_CSTM_HBA "HBA 有無設定
";
CM_ SG_ 1749 CECU6D5_5_7_ADB_ACTIVE "ADB有無設定
";
CM_ SG_ 1749 CECU6D5_4_0_JUDGE_ILL "照度判定
";
CM_ SG_ 1749 CECU6D5_4_1_HEADLAMP_AUTO_SW "ライティングAUTO SW 出力信号
";
CM_ SG_ 1749 CECU6D5_4_2_IND_ACTIVE_HBA "HBA 作動灯
";
CM_ SG_ 1749 CECU6D5_4_4_FGT_LGTOFF_WARNING "ライト消し忘れ警報
";
CM_ SG_ 1749 CECU6D5_3_0_CRN_R_REQ "コーナリングランプR 出力要求
";
CM_ SG_ 1749 CECU6D5_3_2_CRN_L_REQ "コーナリングランプL 出力要求
";
CM_ SG_ 1749 CECU6D5_3_4_FMH "フォローミーホーム出力情報
";
CM_ SG_ 1749 CECU6D5_3_5_LMH "リードミーホーム出力情報
";
CM_ SG_ 1749 CECU6D5_2_0_LGT_1 "ライティング1 リレー出力要求
";
CM_ SG_ 1749 CECU6D5_2_1_LGT_LO "ライティングLo リレー出力要求
";
CM_ SG_ 1749 CECU6D5_2_2_LGT_HI "ライティングHi リレー出力要求
";
CM_ SG_ 1749 CECU6D5_2_4_FFOG_RELAY_REQ "Fフォグランプリレー出力要求
";
CM_ SG_ 1749 CECU6D5_2_5_RFOG_RELAY_REQ "Rフォグランプリレー出力要求
";
CM_ SG_ 1749 CECU6D5_2_6_LGT_DRL "DRL リレー出力要求
";
CM_ SG_ 1749 CECU6D5_1_0_MSG_COUNTER "ﾒｯｾｰｼﾞｶｳﾝﾀ
";
CM_ SG_ 1749 CECU6D5_0_0_CHECK_SUM "ﾁｪｯｸｻﾑ
";
CM_ SG_ 1753 CECU6D9_2_0_RCC_DOOR_LOCK_REQ "RCC ドアロック要求
";
CM_ SG_ 1753 CECU6D9_2_1_RCC_KEY_SEARCH_REQ "RCC アクセスキー確認要求
";
CM_ SG_ 1753 CECU6D9_2_2_RCC_BWAM_SETTING "バッテリ温調設定
";
CM_ SG_ 1753 CECU6D9_1_0_MSG_COUNTER "ﾒｯｾｰｼﾞｶｳﾝﾀ
";
CM_ SG_ 1753 CECU6D9_1_4_RCC_FLG "RCC実行中フラグ
";
CM_ SG_ 1753 CECU6D9_0_0_CHECK_SUM "ﾁｪｯｸｻﾑ
";
CM_ SG_ 723 CECU2D3_2_0_IGA_ON_REQUEST "IGaON要求
";
CM_ SG_ 723 CECU2D3_2_1_IGA_OFF_REQUEST "IGaOFF要求
";
CM_ SG_ 723 CECU2D3_2_2_IGB_ON_REQUEST "IGbON要求
";
CM_ SG_ 723 CECU2D3_2_3_IGB_OFF_REQUEST "IGbOFF要求
";
CM_ SG_ 723 CECU2D3_2_4_READY_ON_REQUEST "ReadyON要求
";
CM_ SG_ 723 CECU2D3_2_5_IGA_STATE "IGa状態
";
CM_ SG_ 723 CECU2D3_2_6_IGB_STATE "IGb状態
";
CM_ SG_ 723 CECU2D3_2_7_FACT_MODE "電源遷移制限モード
";
CM_ SG_ 723 CECU2D3_1_0_MSG_COUNTER "ﾒｯｾｰｼﾞｶｳﾝﾀ
";
CM_ SG_ 723 CECU2D3_0_0_CHECK_SUM "ﾁｪｯｸｻﾑ
";
CM_ SG_ 1748 CECU6D4_4_0_TARGET_POS_PRG "PRG作動停止位置(目標位置)
";
CM_ SG_ 1748 CECU6D4_2_0_REQ_PRG_STOP "PRG作動停止要求
";
CM_ SG_ 1748 CECU6D4_2_1_REQ_PRG_ACT "PRG作動要求
";
CM_ SG_ 1748 CECU6D4_1_0_MSG_COUNTER "メッセージカウンタ
";
CM_ SG_ 1748 CECU6D4_0_0_CHECK_SUM "チェックサム
";
CM_ SG_ 1757 CECU6DD_3_0_PROHIBIT_TLT_SEAT "シート：　作動禁止要求　TLT
";
CM_ SG_ 1757 CECU6DD_3_2_PROHIBIT_LFT_SEAT "シート：　作動禁止要求　LFT
";
CM_ SG_ 1757 CECU6DD_3_4_PROHIBIT_RCL_SEAT "シート：　作動禁止要求　RCL
";
CM_ SG_ 1757 CECU6DD_3_6_PROHIBIT_SLD_SEAT "シート：　作動禁止要求　SLD
";
CM_ SG_ 1757 CECU6DD_2_0_VEHICLE_RUN "走行情報
";
CM_ SG_ 1757 CECU6DD_1_0_MSG_COUNTER "メッセージカウンタ
";
CM_ SG_ 1757 CECU6DD_0_0_CHECK_SUM "チェックサム
";
CM_ SG_ 1756 CECU6DC_7_2_REQ_ACT_CTL_R "Rカーテシランプ作動指示
";
CM_ SG_ 1756 CECU6DC_7_3_REQ_ACT_CTL_L "Lカーテシランプ作動指示
";
CM_ SG_ 1756 CECU6DC_7_4_REQ_ACT_MIR_AFOLD "電動格納作動指示
";
CM_ SG_ 1756 CECU6DC_6_0_TARGET_POS_MIR_RMR "R鏡面作動目標位置
";
CM_ SG_ 1756 CECU6DC_4_0_TARGET_POS_MIR_LMR "L鏡面作動目標位置
";
CM_ SG_ 1756 CECU6DC_2_0_ENBL_POS_REQ_MIR_RMR "R鏡面位置指示有無
";
CM_ SG_ 1756 CECU6DC_2_1_REQ_ACT_MIR_RMR "R鏡面作動指示
";
CM_ SG_ 1756 CECU6DC_2_4_ENBL_POS_REQ_MIR_LMR "L鏡面位置指示有無
";
CM_ SG_ 1756 CECU6DC_2_5_REQ_ACT_MIR_LMR "L鏡面作動指示
";
CM_ SG_ 1756 CECU6DC_1_0_MSG_COUNTER "メッセージカウンタ
";
CM_ SG_ 1756 CECU6DC_0_0_CHECK_SUM "チェックサム
";
CM_ SG_ 1755 CECU6DB_7_0_TARGET_POS_TLT_SEAT "シート：　作動停止位置 TLT
";
CM_ SG_ 1755 CECU6DB_5_0_REQ_ACT_TLT_SEAT "シート：　作動要求 TLT
";
CM_ SG_ 1755 CECU6DB_4_0_TARGET_POS_LFT_SEAT "シート：　作動停止位置 LFT
";
CM_ SG_ 1755 CECU6DB_2_0_REQ_ACT_LFT_SEAT "シート：　作動要求 LFT
";
CM_ SG_ 1755 CECU6DB_1_0_MSG_COUNTER "メッセージカウンタ
";
CM_ SG_ 1755 CECU6DB_0_0_CHECK_SUM "チェックサム
";
CM_ SG_ 1754 CECU6DA_7_0_TARGET_POS_RCL_SEAT "シート：　作動停止位置 RCL
";
CM_ SG_ 1754 CECU6DA_5_0_REQ_ACT_RCL_SEAT "シート：　作動要求 RCL
";
CM_ SG_ 1754 CECU6DA_4_0_TARGET_POS_SLD_SEAT "シート：　作動停止位置 SLD
";
CM_ SG_ 1754 CECU6DA_2_0_REQ_ACT_SLD_SEAT "シート：　作動要求 SLD
";
CM_ SG_ 1754 CECU6DA_1_0_MSG_COUNTER "メッセージカウンタ
";
CM_ SG_ 1754 CECU6DA_0_0_CHECK_SUM "チェックサム
";
CM_ SG_ 1738 CECU6CA_5_2_REQ_DEV "利用者認証デバイス
";
CM_ SG_ 1738 CECU6CA_5_6_REQ_OWCQ "利用者認証要求
";
CM_ SG_ 1738 CECU6CA_4_0_RGMDDK1_CECU "デバイス登録要求_CECU
";
CM_ SG_ 1738 CECU6CA_2_0_ID_D_DEL "消去対象SlotIdentifier
";
CM_ SG_ 1738 CECU6CA_0_0_RQRGDK "デバイス登録要求
";
CM_ SG_ 1576 CECU628_3_4_CAN_MCC "MobileCountryCode
";
CM_ SG_ 1576 CECU628_1_0_MSG_COUNTER "メッセージカウンタ
";
CM_ SG_ 1576 CECU628_0_0_CHECKSUM "チェックサム
";
CM_ SG_ 1739 DCM6CB_7_0 "Reserve
";
CM_ SG_ 1739 DCM6CB_5_0_DKY_SLOT_ID "Degital Key SlotID
";
CM_ SG_ 1739 DCM6CB_4_0_DKY_COM_REQ "Degital Keyコマンド要求
";
CM_ SG_ 1739 DCM6CB_3_5_PNC_SW_REQ_SRV "SVISからのPnCサービスOnOff切替要求
";
CM_ SG_ 1739 DCM6CB_2_0_SHUTDOWN_REQ "リモートシャットダウン要求
";
CM_ SG_ 1739 DCM6CB_2_3_IGB_OFF_REQUEST "IGb OFF電源遷移要求
";
CM_ SG_ 1739 DCM6CB_2_4_IGB_ON_REQUEST "IGb ON電源遷移要求
";
CM_ SG_ 1739 DCM6CB_2_5_REARGATE_UNLOCK_REQ "ﾘﾓｰﾄﾘｱｹﾞｰﾄｱﾝﾛｯｸ要求
";
CM_ SG_ 1739 DCM6CB_2_6_DOOR_UNLOCK_REQ "ﾘﾓｰﾄﾄﾞｱｱﾝﾛｯｸ要求
";
CM_ SG_ 1739 DCM6CB_2_7_DOOR_LOCK_REQUEST "ﾘﾓｰﾄﾄﾞｱﾛｯｸ要求
";
CM_ SG_ 1739 DCM6CB_1_0_MSG_COUNTER "ﾒｯｾｰｼﾞｶｳﾝﾀ
";
CM_ SG_ 1739 DCM6CB_1_4_REQ_SVR_HAZARD_ON "次世代盗難車両追跡用ハザード点滅要求
";
CM_ SG_ 1739 DCM6CB_1_5_HORNHZRD_DEACT_REQ "ﾘﾓｰﾄﾎｰﾝ&ﾊｻﾞｰﾄﾞ停止要求
";
CM_ SG_ 1739 DCM6CB_1_6_HAZARD_ACT_REQ "ﾘﾓｰﾄﾊｻﾞｰﾄﾞ動作要求
";
CM_ SG_ 1739 DCM6CB_1_7_HORNHAZARD_ACT_REQ "ﾘﾓｰﾄﾎｰﾝ&ﾊｻﾞｰﾄﾞ動作要求
";
CM_ SG_ 1739 DCM6CB_0_0_CHECK_SUM "ﾁｪｯｸｻﾑ
";
CM_ SG_ 1361 EAM551_0_0_NETWORK_STATUS "ﾈｯﾄﾜｰｸｽﾃｰﾀｽ
";
CM_ SG_ 1677 MET68D_7_0_STATUS_WASHER_LAMP "ｳｫｯｼｬ残量警告灯状態
";
CM_ SG_ 1677 MET68D_7_1_OILPRESSURE_SW "ｵｲﾙﾌﾟﾚｯｼｬSW状態
";
CM_ SG_ 1677 MET68D_7_2_FLG_EAM "EAM車両装備情報
";
CM_ SG_ 1677 MET68D_7_3_CSTM_IND_RED "ｱｲｻｲﾄﾓﾆﾀｰ変更設定赤色ｲﾝｼﾞｹｰﾀ
";
CM_ SG_ 1677 MET68D_7_4_CSTM_IND_YELLOW "ｱｲｻｲﾄﾓﾆﾀｰ変更設定黄色ｲﾝｼﾞｹｰﾀ
";
CM_ SG_ 1677 MET68D_7_5_CSTM_IND_GREEN "ｱｲｻｲﾄﾓﾆﾀｰ変更設定緑色ｲﾝｼﾞｹｰﾀ
";
CM_ SG_ 1677 MET68D_7_6_REQ_CSTM_SRH "SRHｶｽﾀﾏｲｽﾞ変更要求
";
CM_ SG_ 1677 MET68D_7_7_CSTM_SRH "SRHｶｽﾀﾏｲｽﾞ変更設定
";
CM_ SG_ 1677 MET68D_6_5_REQ_CHG_CSTM_RAB "RABｶｽﾀﾏｲｽﾞ要求変更
";
CM_ SG_ 1677 MET68D_6_6_CSTM_RAB "ｿﾅｰｶｽﾀﾏｲｽﾞ変更設定(RABON/OFF)
";
CM_ SG_ 1677 MET68D_6_7_CSTM_SONNER "ｿﾅｰｶｽﾀﾏｲｽﾞ変更設定(ｿﾅｰON/OFF)
";
CM_ SG_ 1677 MET68D_5_0_TEMP_FOR_PPA "歩行者保護A/B用温度
";
CM_ SG_ 1677 MET68D_2_0_ODO "ｵﾄﾞﾒｰﾀ値
";
CM_ SG_ 1677 MET68D_1_0_MSG_COUNTER "ﾒｯｾｰｼﾞｶｳﾝﾀ
";
CM_ SG_ 1677 MET68D_1_4_RESET_CSTM_TPMS_RAEB "ｶｽﾀﾏｲｽﾞﾘｾｯﾄ要求(TPMS/RAEB)
";
CM_ SG_ 1677 MET68D_1_5_REQ_CHG_CSTM_TPMS "TPMSｶｽﾀﾏｲｽﾞ要求変更
";
CM_ SG_ 1677 MET68D_1_6_CSTM_TIRE_UNIT "ﾀｲﾔ空気圧表示単位設定
";
CM_ SG_ 1677 MET68D_0_0_CHECK_SUM "ﾁｪｯｸｻﾑ
";
CM_ SG_ 1676 MET68C_7_0_CSTM_OUTTEMP "外気温ｶｽﾀﾏｲｽﾞ設定値
";
CM_ SG_ 1676 MET68C_4_6_UNIT_DEGREE "外気温単位設定値
";
CM_ SG_ 1676 MET68C_3_0_MET_SW_STATE "ﾒｰﾀSW操作状態ﾌﾗｸﾞ
";
CM_ SG_ 1676 MET68C_3_3_PERMIT_MFD_CSTM "MFDｶｽﾀﾏｲｽﾞ許可ﾌﾗｸﾞ
";
CM_ SG_ 1676 MET68C_3_5_FLG_RR_AC_PANEL "リアﾋｰｺﾝﾊﾟﾈﾙ装備
";
CM_ SG_ 1676 MET68C_3_6_FLG_SEAT_VENT "シート空調装備情報
";
CM_ SG_ 1676 MET68C_3_7_FLG_SEAT_HEAT "ｼｰﾄﾋｰﾀ装備情報
";
CM_ SG_ 1676 MET68C_2_0_CRUISING_RADIUS "航続可能距離表示値
";
CM_ SG_ 1676 MET68C_1_0_MSG_COUNTER "ﾒｯｾｰｼﾞｶｳﾝﾀ
";
CM_ SG_ 1676 MET68C_1_4_CSTM_HU "HU有無ﾌﾗｸﾞ
";
CM_ SG_ 1676 MET68C_1_5_CSTM_BRAND_NAME "ブランドフラグ
";
CM_ SG_ 1676 MET68C_0_0_CHECK_SUM "ﾁｪｯｸｻﾑ
";
CM_ SG_ 915 MET393_7_0_REQ_CHG_CSTM_EYE "ｱｲｻｲﾄｶｽﾀﾏｲｽﾞ要求変更
";
CM_ SG_ 915 MET393_7_1_REQ_RESET_CSTM_EYE "ｱｲｻｲﾄｶｽﾀﾏｲｽﾞﾘｾｯﾄ要求
";
CM_ SG_ 915 MET393_7_2_CSTM_ALK "ｱｲｻｲﾄｶｽﾀﾏｲｽﾞ変更設定(車線中央維持)
";
CM_ SG_ 915 MET393_7_3_CSTM_HBA "ｱｲｻｲﾄｶｽﾀﾏｲｽﾞ変更設定値(HBA)
";
CM_ SG_ 915 MET393_7_4_CSTM_MIS_AT_BACK "ｱｲｻｲﾄｶｽﾀﾏｲｽﾞ変更設定(AT誤後進抑制制御)
";
CM_ SG_ 915 MET393_7_6_CSTM_ACC_CONT "ｱｲｻｲﾄｶｽﾀﾏｲｽﾞ変更設定(ACC加速特性)
";
CM_ SG_ 915 MET393_6_0_R_DIFF_TEMP "R.DIFF油温ｾﾝｻ
";
CM_ SG_ 915 MET393_5_2_WARN_R_DIFF_TEMP "R.DIFF油温警告灯
";
CM_ SG_ 915 MET393_5_4_ADAPTIVECC_NOALIVE "追従ｸﾙｺﾝ未着判定ﾌﾗｸﾞ
";
CM_ SG_ 915 MET393_5_5_DUAL_RANGE_LO "ﾃﾞｭｱﾙﾚﾝｼﾞLo
";
CM_ SG_ 915 MET393_5_6_CSTM_SPD_LIMITER "ｱｲｻｲﾄｶｽﾀﾏｲｽﾞ変更設定(SAS)
";
CM_ SG_ 915 MET393_5_7_CSTM_LANE_CONT "ｱｲｻｲﾄｶｽﾀﾏｲｽﾞ変更設定(通行車線)
";
CM_ SG_ 915 MET393_4_0_FUEL_LEVEL_RESIST "燃料ﾚﾍﾞﾙｾﾝｻ抵抗値
";
CM_ SG_ 915 MET393_3_5_SI_DRIVE_SW "SI-DRIVE SW情報
";
CM_ SG_ 915 MET393_2_0_OUTTEMP_FOR_DIAG "診断用外気温
";
CM_ SG_ 915 MET393_1_0_MSG_COUNTER "ﾒｯｾｰｼﾞｶｳﾝﾀ
";
CM_ SG_ 915 MET393_1_4_CSTM_IND_BLUE "ｱｲｻｲﾄﾓﾆﾀｰ変更設定青色ｲﾝｼﾞｹｰﾀ
";
CM_ SG_ 915 MET393_1_5_CSTM_AES_CONT "ｱｲｻｲﾄｶｽﾀﾏｲｽﾞ変更設定(AES)
";
CM_ SG_ 915 MET393_1_6_FLG_PEDESTRIAN_AIRBAG "歩行者保護A/B有無ﾌﾗｸﾞ
";
CM_ SG_ 915 MET393_0_0_CHECK_SUM "ﾁｪｯｸｻﾑ
";
CM_ SG_ 912 MET390_7_0_VDC_ON_OFF "VDC SW情報
";
CM_ SG_ 912 MET390_7_2_RR_DOOR_RECORD_L "後席ﾄﾞｱ開履歴送信（左）
";
CM_ SG_ 912 MET390_7_3_RR_DOOR_RECORD_R "後席ﾄﾞｱ開履歴送信（右）
";
CM_ SG_ 912 MET390_7_4_REQ_CHG_CSTM_PSM "PSMｶｽﾀﾏｲｽﾞ要求変更
";
CM_ SG_ 912 MET390_7_5_REQ_RESET_CSTM_PSM "PSM　ｶｽﾀﾏｲｽﾞﾘｾｯﾄ要求
";
CM_ SG_ 912 MET390_7_6_CSTM_MIR_AFOLD_CONT "ﾄﾞｱﾐﾗｰｶｽﾀﾏｲｽﾞ変更設定(ｵｰﾄ電動格納ﾐﾗｰ)
";
CM_ SG_ 912 MET390_7_7_CSTM_MIR_RTILT_CONT "ﾄﾞｱﾐﾗｰｶｽﾀﾏｲｽﾞ変更設定(ﾘﾊﾞｰｽ連動ﾐﾗｰ)
";
CM_ SG_ 912 MET390_6_0_SEATBELT_DRVR "ｼｰﾄﾍﾞﾙﾄﾊﾞｯｸﾙSW　D席
";
CM_ SG_ 912 MET390_6_1_SEATBELT_PASS "ｼｰﾄﾍﾞﾙﾄﾊﾞｯｸﾙSW　P席
";
CM_ SG_ 912 MET390_6_2_TURN_SIG_LEFT "ﾀｰﾝ左出力信号
";
CM_ SG_ 912 MET390_6_3_TURN_SIG_RIGHT "ﾀｰﾝ右出力信号
";
CM_ SG_ 912 MET390_6_4_BRIGHT_SW "ﾌﾞﾗｲﾄ信号
";
CM_ SG_ 912 MET390_6_5_FAIL_UART_WA_BOX "WA-BOX UART通信異常
";
CM_ SG_ 912 MET390_6_6_ISS_OFF_SW "ISS OFFｽｲｯﾁ状態
";
CM_ SG_ 912 MET390_6_7_FLG_DMS "DMS車両装備情報
";
CM_ SG_ 912 MET390_5_0_ILL_BRIGHTNESS "ｲﾙﾐ輝度値
";
CM_ SG_ 912 MET390_4_0_OUTTEMP_FOR_IND "表示用外気温
";
CM_ SG_ 912 MET390_3_0_UNIT_SPEED_TRIP "速度計/距離計表示単位
";
CM_ SG_ 912 MET390_3_1_FLG_EYESIGHT "EyeSightﾌﾗｸﾞ
";
CM_ SG_ 912 MET390_3_2_FLG_ISS "ISSﾌﾗｸﾞ
";
CM_ SG_ 912 MET390_3_3_FLG_HEV "HEVﾌﾗｸﾞ
";
CM_ SG_ 912 MET390_3_4_FLG_IMB "IMﾌﾗｸﾞ
";
CM_ SG_ 912 MET390_3_5_TIRE_SIZE "ﾀｲﾔ径情報
";
CM_ SG_ 912 MET390_3_6_FLG_XMODE "Xモード車両装備情報
";
CM_ SG_ 912 MET390_2_0_VEHICLE_SERIES "車型情報
";
CM_ SG_ 912 MET390_2_3_DESTINATION "仕向地情報
";
CM_ SG_ 912 MET390_2_7_PASS_DOOR_RECORD "助手席ﾄﾞｱ開履歴送信
";
CM_ SG_ 912 MET390_1_0_MSG_COUNTER "ﾒｯｾｰｼﾞｶｳﾝﾀ
";
CM_ SG_ 912 MET390_1_4_WAKE_UP_FRAME "ｳｪｲｸｱｯﾌﾟﾌﾚｰﾑ識別ﾌﾗｸﾞ
";
CM_ SG_ 912 MET390_1_5_REQ_COMM_CONT "通信継続要求ﾌﾗｸﾞ
";
CM_ SG_ 912 MET390_1_6_DMS_ID_SET "DMS ID設定完了ﾌﾗｸﾞ
";
CM_ SG_ 912 MET390_1_7_FAIL_EEPROM "EEPROMﾌｪｰﾙ
";
CM_ SG_ 912 MET390_0_0_CHECK_SUM "ﾁｪｯｸｻﾑ
";
CM_ SG_ 937 MET3A9_3_5_DAY_NIGHT_STATE "昼夜状態
";
CM_ SG_ 937 MET3A9_3_0_ILL_LEVEL "ｲﾙﾐ段数
";
CM_ SG_ 937 MET3A9_2_0_ILL_VALUE "ｲﾙﾐ輝度値
";
CM_ SG_ 937 MET3A9_1_7_BRIGHT_STATE "ﾌﾞﾗｲﾄ状態
";
CM_ SG_ 937 MET3A9_1_6_UI_THEME_STATE "UI Theme状態
";
CM_ SG_ 937 MET3A9_1_0_MSG_COUNTER "ﾒｯｾｰｼﾞｶｳﾝﾀ
";
CM_ SG_ 937 MET3A9_0_0_CHECKSUM "ﾁｪｯｸｻﾑ
";
CM_ SG_ 933 MET3A5_7_0_INSTCNSP_VAL "瞬間燃費
";
CM_ SG_ 933 MET3A5_5_0_AVEN_TRIPB_VAL "平均燃費(TRIP B)
";
CM_ SG_ 933 MET3A5_3_0_AVEN_TRIPA_VAL "平均燃費(TRIP A)
";
CM_ SG_ 933 MET3A5_2_0_E2E_COUNTER "E2Eｶｳﾝﾀ
";
CM_ SG_ 933 MET3A5_0_0_CRC "CRC
";
CM_ SG_ 1614 RKE64E_6_0_BUZ_1SHOT_IN "室内ﾌﾞｻﾞｰ　単発1回吹鳴要求
";
CM_ SG_ 1614 RKE64E_6_1_BUZ_2SHOT_IN "室内ﾌﾞｻﾞｰ　単発2回吹鳴要求
";
CM_ SG_ 1614 RKE64E_6_2_REQ_WARNG_BAT_POWER "電池残量警告表示要求
";
CM_ SG_ 1614 RKE64E_4_0_TRANS_ID "送信機ID
";
CM_ SG_ 1614 RKE64E_4_3_COUNTER "ｶｳﾝﾀ値
";
CM_ SG_ 1614 RKE64E_4_5_TIME_ON_SW_KEY_LESS "SW ON時間
";
CM_ SG_ 1614 RKE64E_3_0_REQ_NOMAL_KEY_LESS "ﾉｰﾏﾙｷｰﾚｽ要求
";
CM_ SG_ 1614 RKE64E_1_0_MSG_COUNTER "ﾒｯｾｰｼﾞｶｳﾝﾀ
";
CM_ SG_ 1614 RKE64E_1_4_WAKE_UP_FRAME "ｳｪｲｸｱｯﾌﾟﾌﾚｰﾑ識別ﾌﾗｸﾞ
";
CM_ SG_ 1614 RKE64E_1_5_REQ_COMM_CONT "通信継続要求ﾌﾗｸﾞ
";
CM_ SG_ 1614 RKE64E_1_6 "予約:通信継続要求ﾌﾗｸﾞ(拡張)
";
CM_ SG_ 1614 RKE64E_0_0_CHECK_SUM "ﾁｪｯｸｻﾑ
";
CM_ SG_ 1285 RKE505_1_4_ActiveWakeUpBit "Active Wakeup ﾌﾗｸﾞ
";
CM_ SG_ 1285 RKE505_0_0_SourceNodeID "送信元ID
";
CM_ SG_ 1658 TPM67A_6_1_TIRE_COLOR_RR "ﾀｲﾔRR表示　色
";
CM_ SG_ 1658 TPM67A_6_5_TIRE_COLOR_RL "ﾀｲﾔRL表示 色
";
CM_ SG_ 1658 TPM67A_6_7_TIRE_PRESSURE_RL "ﾀｲﾔRL 空気圧表示
";
CM_ SG_ 1658 TPM67A_5_0_TIRE_PRESSURE_RR "ﾀｲﾔRR 空気圧表示
";
CM_ SG_ 1658 TPM67A_3_1_TIRE_COLOR_FL "ﾀｲﾔFL表示 色
";
CM_ SG_ 1658 TPM67A_3_5_TIRE_COLOR_FR "ﾀｲﾔFR表示 色
";
CM_ SG_ 1658 TPM67A_3_7_TIRE_PRESSURE_FR "ﾀｲﾔFR 空気圧表示
";
CM_ SG_ 1658 TPM67A_2_0_TIRE_PRESSURE_FL "ﾀｲﾔFL 空気圧表示
";
CM_ SG_ 1658 TPM67A_1_0_MSG_COUNTER "ﾒｯｾｰｼﾞｶｳﾝﾀ
";
CM_ SG_ 1658 TPM67A_1_5_UNIT_IND_PRESSURE "空気圧表示単位
";
CM_ SG_ 1658 TPM67A_1_7_IND_PRESSURE "空気圧表示有無ﾌﾗｸﾞ
";
CM_ SG_ 1658 TPM67A_0_0_CHECK_SUM "ﾁｪｯｸｻﾑ
";
CM_ SG_ 1657 TPM679_3_0_STATE_TPMS "TPMS状態ﾌﾗｸﾞ
";
CM_ SG_ 1657 TPM679_3_2_DEFINED_STATE_TPMS "TPMS状態確定
";
CM_ SG_ 1657 TPM679_3_4_MODE_SELECT_TPMS "TPMSカスタマイズMode種別
";
CM_ SG_ 1657 TPM679_2_0_WARN_TPMS "TPMSｳｫｰﾆﾝｸﾞ
";
CM_ SG_ 1657 TPM679_2_3_INTERRUPT "割り込み表示
";
CM_ SG_ 1657 TPM679_2_5_CHECKLUMP_TPMS "TPMSチェックランプ点灯信号
";
CM_ SG_ 1657 TPM679_1_0_MSG_COUNTER "ﾒｯｾｰｼﾞｶｳﾝﾀ
";
CM_ SG_ 1657 TPM679_1_6 "予約:通信継続要求ﾌﾗｸﾞ(拡張)
";
CM_ SG_ 1657 TPM679_0_0_CHECK_SUM "ﾁｪｯｸｻﾑ
";
CM_ SG_ 827 ABG33B_4_0_PASSENGER_BELT_INFO "助手席シートベルト情報
";
CM_ SG_ 827 ABG33B_4_2_PASSENGER_DETECT_INFO "助手席乗員判定情報
";
CM_ SG_ 827 ABG33B_3_0_PPS_STATUS_FAIL_IGN "歩行者保護A/B故障有無状態（点火）
";
CM_ SG_ 827 ABG33B_3_1_PPS_STATUS_FAIL_DEV "歩行者保護A/B故障有無状態（ﾃﾞﾊﾞｲｽ）
";
CM_ SG_ 827 ABG33B_3_2_PPS_STATUS_FAIL_SSR "歩行者保護A/B故障有無状態（ｾﾝｻ）
";
CM_ SG_ 827 ABG33B_3_3_PPS_STATUS_FAIL_ECU "歩行者保護A/B故障有無状態（ECU）
";
CM_ SG_ 827 ABG33B_2_0_IND_WARN_PPA "歩行者ｴｱﾊﾞｯｸﾞｳｫｰﾆﾝｸﾞﾗﾝﾌﾟ点灯・点滅要求
";
CM_ SG_ 827 ABG33B_2_2_DETECT_CRUSH "衝突検知信号(歩行者)
";
CM_ SG_ 827 ABG33B_1_0_MSG_COUNTER "ﾒｯｾｰｼﾞｶｳﾝﾀ
";
CM_ SG_ 827 ABG33B_1_4_FLG_PEDESTRIAN_AIRBAG "歩行者保護A/B有無ﾌﾗｸﾞ
";
CM_ SG_ 827 ABG33B_1_6 "予約:通信継続要求ﾌﾗｸﾞ(拡張)
";
CM_ SG_ 827 ABG33B_0_0_CHECK_SUM "ﾁｪｯｸｻﾑ
";
CM_ SG_ 826 ABG33A_7_0_VELOCITYCHANGE_VX_MAX "衝突時ΔVx MAX
";
CM_ SG_ 826 ABG33A_6_0_VELOCITYCHANGE_VX_MAX "衝突時ΔVx MAX
";
CM_ SG_ 826 ABG33A_5_0_P_SIDE_ABG_DEPLOY "P席ｻｲﾄﾞｴｱﾊﾞｯｸﾞ展開判定
";
CM_ SG_ 826 ABG33A_5_1_D_SIDE_ABG_DEPLOY "D席ｻｲﾄﾞｴｱﾊﾞｯｸﾞ展開判定
";
CM_ SG_ 826 ABG33A_5_2_FRONT_FAR_ABG_DEPLOY "前席ﾌｧｰｻｲﾄﾞｴｱﾊﾞｯｸﾞ展開判定
";
CM_ SG_ 826 ABG33A_5_3_REAR_FAR_ABG_DEPLOY "後席ﾌｧｰｻｲﾄﾞｴｱﾊﾞｯｸﾞ展開判定
";
CM_ SG_ 826 ABG33A_5_4_REAR_RH_ABG_DEPLOY "後席ｻｲﾄﾞｴｱﾊﾞｯｸﾞRH展開判定
";
CM_ SG_ 826 ABG33A_5_5_REAR_LH_ABG_DEPLOY "後席ｻｲﾄﾞｴｱﾊﾞｯｸﾞLH展開判定
";
CM_ SG_ 826 ABG33A_5_6_P_CURTAIN_ABG_DEPLOY "P席ｶｰﾃﾝｴｱﾊﾞｯｸﾞ展開判定
";
CM_ SG_ 826 ABG33A_5_7_D_CURTAIN_ABG_DEPLOY "D席ｶｰﾃﾝｴｱﾊﾞｯｸﾞ展開判定
";
CM_ SG_ 826 ABG33A_4_0_D_FRONT_ABG_DEPLOY "D席ﾌﾛﾝﾄｴｱﾊﾞｯｸﾞ展開判定
";
CM_ SG_ 826 ABG33A_4_1_P_FRONT_ABG_DEPLOY "P席ﾌﾛﾝﾄｴｱﾊﾞｯｸﾞ展開判定
";
CM_ SG_ 826 ABG33A_4_2_P_ABG_DEPLOY "P席ｼｰﾄｸｯｼｮﾝｴｱﾊﾞｯｸﾞ展開判定
";
CM_ SG_ 826 ABG33A_4_3_D_ABG_DEPLOY "D席ｼｰﾄｸｯｼｮﾝｴｱﾊﾞｯｸﾞ展開判定
";
CM_ SG_ 826 ABG33A_4_4_P_BELT_PRETENTION "P席ｼｰﾄﾍﾞﾙﾄﾌﾟﾘﾃﾝｼｮﾅ展開判定
";
CM_ SG_ 826 ABG33A_4_5_D_BELT_PRETENTION "D席ｼｰﾄﾍﾞﾙﾄﾌﾟﾘﾃﾝｼｮﾅ展開判定
";
CM_ SG_ 826 ABG33A_4_6_D_KNEE_ABG_DEPLOY "D席ﾆｰｴｱﾊﾞｯｸﾞ展開判定
";
CM_ SG_ 826 ABG33A_4_7_P_KNEE_ABG_DEPLOY "P席ﾆｰｴｱﾊﾞｯｸﾞ展開判定
";
CM_ SG_ 826 ABG33A_3_0_BELT_WRNING_PASS "P席ﾍﾞﾙﾄ状態(ｳｫｰﾆﾝｸﾞ出力用)
";
CM_ SG_ 826 ABG33A_3_2_BUCKLESW_DRVR "D席ﾊﾞｯｸﾙｽｲｯﾁ
";
CM_ SG_ 826 ABG33A_3_4_OCCUPATION_PASS "P席乗員有無信号
";
CM_ SG_ 826 ABG33A_3_6_IND_ACT_ABG_PASS "P席A/B作動ﾓｰﾄﾞｲﾝｼﾞｹｰﾀ
";
CM_ SG_ 826 ABG33A_2_0_IND_WARN_ABG "ｴｱﾊﾞｯｸﾞｳｫｰﾆﾝｸﾞﾗﾝﾌﾟ点灯・点滅要求
";
CM_ SG_ 826 ABG33A_2_2_DETECT_CRUSH "衝突検知信号
";
CM_ SG_ 826 ABG33A_2_5_STATUS_CRUSH_ECALL "衝突形態
";
CM_ SG_ 826 ABG33A_1_0_MSG_COUNTER "ﾒｯｾｰｼﾞｶｳﾝﾀ
";
CM_ SG_ 826 ABG33A_1_4_FLG_ABGIND_CTRL "P席 A/B ON/OFFｲﾝｼﾞｹｰﾀ点灯要求有無ﾌﾗｸﾞ
";
CM_ SG_ 826 ABG33A_1_5_REQ_COMM_CONT "通信継続要求
";
CM_ SG_ 826 ABG33A_1_6_COLLISION_COUNTER "衝突判定回数
";
CM_ SG_ 826 ABG33A_0_0_CHECK_SUM "ﾁｪｯｸｻﾑ
";
CM_ SG_ 961 DMS3C1_7_4_SHORT_DIST_DETECT "ショートディストラクション判定フラグ
";
CM_ SG_ 961 DMS3C1_7_5_PRESENCE_DETECT "後席乗員検知情報
";
CM_ SG_ 961 DMS3C1_7_6_RADER_EQUIP "ミリ波搭載情報
";
CM_ SG_ 961 DMS3C1_7_7_LOSING_POSTURE_DETECT "異常姿勢検知フラグ
";
CM_ SG_ 961 DMS3C1_6_0_ID_RECOG_CANCEL "ID認識中断フラグ
";
CM_ SG_ 961 DMS3C1_6_1_ID_ENABLE_FLAG "ID有効フラグ
";
CM_ SG_ 961 DMS3C1_6_2_PERMIT_AVN_FLAG "AVN操作許可フラグ
";
CM_ SG_ 961 DMS3C1_6_4_DISTRACTION_STATUS "脇見状態フラグ
";
CM_ SG_ 961 DMS3C1_6_5_DROWSINESS_STATUS "閉眼状態フラグ
";
CM_ SG_ 961 DMS3C1_6_6_DROWSINESS_LV2_STATUS "強い眠気状態フラグ
";
CM_ SG_ 961 DMS3C1_6_7_NOT_DETECTED_STATUS "顔未検出状態フラグ
";
CM_ SG_ 961 DMS3C1_5_0_ID_LIST "ID登録リスト
";
CM_ SG_ 961 DMS3C1_5_5_ID_EDIT_FLAG "ID設定フラグ
";
CM_ SG_ 961 DMS3C1_4_0_DMS_IND_REQ_FLAG "インジゲータ点灯フラグ
";
CM_ SG_ 961 DMS3C1_4_3_DMS_RECOG_STATUS "個人認識ON/OFF状態
";
CM_ SG_ 961 DMS3C1_4_4_DRIVER_STATUS "D席乗員状態
";
CM_ SG_ 961 DMS3C1_3_0_DRIVER_REGIST_ID "個人ID
";
CM_ SG_ 961 DMS3C1_3_4_CUST_EDIT_FLAG "カスタマイズ操作フラグ
";
CM_ SG_ 961 DMS3C1_3_6_ID_RECOG_FLAG "ID識別フラグ
";
CM_ SG_ 961 DMS3C1_2_0_LEVEL_DROWS "居眠り深度
";
CM_ SG_ 961 DMS3C1_2_3_DROWS_DETECT_FLAG "居眠り判定フラグ
";
CM_ SG_ 961 DMS3C1_2_7_DIST_DETECT_FLAG "脇見判定フラグ
";
CM_ SG_ 961 DMS3C1_1_0_MSG_COUNTER "メッセージカウンタ
";
CM_ SG_ 961 DMS3C1_1_4_WAKE_UP_FRAME "ｳｪｲｸｱｯﾌﾟﾌﾚｰﾑ識別ﾌﾗｸﾞ
";
CM_ SG_ 961 DMS3C1_1_5_REQ_COMM_CONT "通信継続要求ﾌﾗｸﾞ
";
CM_ SG_ 961 DMS3C1_1_7_EYE_DIST_FLAG "早鳴りフラグ
";
CM_ SG_ 961 DMS3C1_0_0_CHKSUM "ﾁｪｯｸｻﾑ
";
CM_ SG_ 1651 ACN673_7_2_REQ_STRG_H "ステアリングヒータ動作要求
";
CM_ SG_ 1651 ACN673_7_1_SEAT_H_L_AUTOIND "シートヒータ空調（左側） AUTOIND点灯
";
CM_ SG_ 1651 ACN673_7_0_SEAT_H_R_AUTOIND "シートヒータ空調（右側） AUTOIND点灯
";
CM_ SG_ 1651 ACN673_6_0_RR_FAN_SYMBOL "RR FAN SYMBOL
";
CM_ SG_ 1651 ACN673_6_2_SEAT_H_R "シートヒータ空調（右側）
";
CM_ SG_ 1651 ACN673_6_5_SEAT_H_L "シートヒータ空調（左側）
";
CM_ SG_ 1651 ACN673_5_0_DR_ONLY "一席集中状態
";
CM_ SG_ 1651 ACN673_5_2_STRG_H "ステアリングヒータ状態
";
CM_ SG_ 1651 ACN673_5_4_AC_SI_DS_SET "SI-DS空調設定
";
CM_ SG_ 1651 ACN673_5_6_STRG_H_AUTOIND "ステアリングヒータ AUTO IND点灯
";
CM_ SG_ 1651 ACN673_5_7_AC_SI_DS_FLG "SI-DS空調有無フラグ
";
CM_ SG_ 1651 ACN673_4_0_SEAT_HEATER_DR "Dr席　シートヒーター作動状態
";
CM_ SG_ 1651 ACN673_4_2_SEAT_HEATER_PA "Pa席　シートヒーター作動状態
";
CM_ SG_ 1651 ACN673_4_4_SEAT_HEATER "シートヒーター有無
";
CM_ SG_ 1651 ACN673_4_5_TEMP_SET_TYPE "設定温度タイプ
";
CM_ SG_ 1651 ACN673_4_7_VENTI_SEAT_EX_HI "シート空調EX-HI
";
CM_ SG_ 1651 ACN673_1_0_MSG_COUNTER "ﾒｯｾｰｼﾞｶｳﾝﾀ
";
CM_ SG_ 1651 ACN673_1_6_SYNC_RR "SYNC_RR
";
CM_ SG_ 1651 ACN673_1_7_RR_LOCK "RR_LOCK
";
CM_ SG_ 1651 ACN673_0_0_CHECK_SUM "ﾁｪｯｸｻﾑ
";
CM_ SG_ 1650 ACN672_7_0_INFO_AUTO3MODE "AUTO3モード
";
CM_ SG_ 1650 ACN672_7_2_INFO_REAR_TEMP "Rr設定温度
";
CM_ SG_ 1650 ACN672_6_0_DEF "DEF
";
CM_ SG_ 1650 ACN672_6_1_FAN_SYMBOL "FAN SYMBOL
";
CM_ SG_ 1650 ACN672_6_2_REAR_MODE "Rr吹き出し口ﾓｰﾄﾞ
";
CM_ SG_ 1650 ACN672_6_4_UNIT_TEMP "温度仕様
";
CM_ SG_ 1650 ACN672_6_5_SPEC_AC_UNIT "空調仕様
";
CM_ SG_ 1650 ACN672_6_7_REAR_AC "ﾘｱ空調有無
";
CM_ SG_ 1650 ACN672_5_0_AC_VR_MODE "ｴｱｺﾝ音声認識ﾓｰﾄﾞ
";
CM_ SG_ 1650 ACN672_5_2_INFO_TEMP_PASS "Pa設定温度
";
CM_ SG_ 1650 ACN672_4_0_AC_INTERRUPT_DISPLAY "ｴｱｺﾝ割り込み画面表示
";
CM_ SG_ 1650 ACN672_4_1_AC_VR_ACTION "ｴｱｺﾝ音声認識ｺﾏﾝﾄﾞ実行
";
CM_ SG_ 1650 ACN672_4_2_INFO_TEMP_DRVR "Dr設定温度
";
CM_ SG_ 1650 ACN672_3_0_MAX_AC "MAX A/C
";
CM_ SG_ 1650 ACN672_3_1_INFO_SYNC_OR_SING "SYNC
";
CM_ SG_ 1650 ACN672_3_2_INFO_FULL_OR_AUTO "FULL及びAUTO
";
CM_ SG_ 1650 ACN672_3_4_INFO_AC_ON "A/C
";
CM_ SG_ 1650 ACN672_3_5_INFO_RDEF "Rrﾃﾞﾌ
";
CM_ SG_ 1650 ACN672_3_6_INFO_CIRCULATION "内外気
";
CM_ SG_ 1650 ACN672_2_0_INFO_MODE_VENT "吹き出し口ﾓｰﾄﾞ
";
CM_ SG_ 1650 ACN672_2_4_INFO_FANONLY "送風モード
";
CM_ SG_ 1650 ACN672_2_5_INFO_LEV_BLOWERFAN "ﾌｧﾝ段数
";
CM_ SG_ 1650 ACN672_1_0_MSG_COUNTER "ﾒｯｾｰｼﾞｶｳﾝﾀ
";
CM_ SG_ 1650 ACN672_1_4_LVL_BLOWERFAN_RR "Rrﾌｧﾝ段数
";
CM_ SG_ 1650 ACN672_1_7_REAR_AUTO "Rr AUTO
";
CM_ SG_ 1650 ACN672_0_0_CHECK_SUM "ﾁｪｯｸｻﾑ
";
CM_ SG_ 722 ACN2D2_7_0_PD_PRESSURE "A/C PD圧力値
";
CM_ SG_ 722 ACN2D2_6_0_TRQ_COMP_ESTM "ｺﾝﾌﾟﾚｯｻﾄﾙｸ推定値
";
CM_ SG_ 722 ACN2D2_5_0_REQ_ENG_RPM "ｴｱｺﾝ要求ｴﾝｼﾞﾝ回転数
";
CM_ SG_ 722 ACN2D2_5_3_REQ_IDLE_COMP_RPM "ｱｲﾄﾞﾙ時要求ｺﾝﾌﾟﾚｯｻ回転数
";
CM_ SG_ 722 ACN2D2_4_0_LVL_PTC "PTC段数 電気負荷情報
";
CM_ SG_ 722 ACN2D2_4_2_MARGIN_OF_AC "ｴｱｺﾝ余裕度
";
CM_ SG_ 722 ACN2D2_4_5_LVL_BLOWER_FAN "ﾌﾞﾛｱﾌｧﾝSW（電気負荷情報）
";
CM_ SG_ 722 ACN2D2_3_0_PERMIT_ISS "ISS作動許可
";
CM_ SG_ 722 ACN2D2_3_2_TRQ_PAT_COMP_ESTM "A/C見込みﾄﾙｸﾊﾟﾀｰﾝ
";
CM_ SG_ 722 ACN2D2_3_5_IND_ROOM_TEMP "室温表示
";
CM_ SG_ 722 ACN2D2_2_0_FAIL_TRQ_COMP_ESTM "ｺﾝﾌﾟﾚｯｻﾄﾙｸ推定値ﾌｪｰﾙ
";
CM_ SG_ 722 ACN2D2_2_1_FAIL_AC "A/Cﾌｪｰﾙ
";
CM_ SG_ 722 ACN2D2_2_2_REQ_INHIBIT_LOCKUP "L/U禁止要求
";
CM_ SG_ 722 ACN2D2_2_3_AC_ON "A/C信号
";
CM_ SG_ 722 ACN2D2_2_4_RDEFOGSW "RﾃﾞﾌｫｯｶﾞSW
";
CM_ SG_ 722 ACN2D2_2_5_WARM_UP "ｳｫｰﾑｱｯﾌﾟ信号
";
CM_ SG_ 722 ACN2D2_2_6_AC_AUTO_MANUAL "ｵｰﾄｴｱｺﾝ・ﾏﾆｭｱﾙｴｱｺﾝ判別信号
";
CM_ SG_ 722 ACN2D2_2_7_COMP_TYPE "ｺﾝﾌﾟﾚｯｻﾀｲﾌﾟ
";
CM_ SG_ 722 ACN2D2_1_0_MSG_COUNTER "ﾒｯｾｰｼﾞｶｳﾝﾀ
";
CM_ SG_ 722 ACN2D2_1_4 "ｳｪｲｸｱｯﾌﾟﾌﾚｰﾑ識別ﾌﾗｸﾞ
";
CM_ SG_ 722 ACN2D2_1_5 "通信継続要求ﾌﾗｸﾞ
";
CM_ SG_ 722 ACN2D2_1_6 "予約:通信継続要求ﾌﾗｸﾞ(拡張)
";
CM_ SG_ 722 ACN2D2_1_7_WARM_POWER_CONT "暖房促進制御信号
";
CM_ SG_ 722 ACN2D2_0_0_CHECK_SUM "ﾁｪｯｸｻﾑ
";
CM_ SG_ 1373 ACN55D_7_0_NETWORK_STATUS "ﾈｯﾄﾜｰｸｽﾃｰﾀｽ
";
CM_ SG_ 1667 ACN683_3_2_AC_DEFALTSET "空調デフォルト設定コマンドフラグ
";
CM_ SG_ 1667 ACN683_3_0_RCC_ACN_RES "テレマリモ空作動結果通知フラグ
";
CM_ SG_ 1667 ACN683_2_7_JUDGE_FANONLY "送風モード作動可否
";
CM_ SG_ 1667 ACN683_2_6_CSTM_LINK_SEAT_R "右側シートヒータ空調AUTO連動カスタマイズ
";
CM_ SG_ 1667 ACN683_2_5_CSTM_LINK_SEAT_L "左側 シートヒータ空調
AUTO連動カスタマイズ
";
CM_ SG_ 1667 ACN683_2_4_CSTM_STRG_H_LINK "ステアリングヒータ
AUTO連動カスタマイズ
";
CM_ SG_ 1667 ACN683_2_2_CSTM_TEMP_SVS_R "右側 シートベンチレーション温度 
カスタマイズ
";
CM_ SG_ 1667 ACN683_2_0_CSTM_TEMP_SVS_L "左側 シートベンチレーション温度 
カスタマイズ
";
CM_ SG_ 1667 ACN683_1_6_CSTM_TEMP_SEAT_H_R "右側 シートヒータ温度 
カスタマイズ
";
CM_ SG_ 1667 ACN683_1_4_CSTM_TEMP_SEAT_H_L "左側 シートヒータ温度
カスタマイズ
";
CM_ SG_ 1667 ACN683_1_0_MSG_COUNTER "メッセージカウンタ
";
CM_ SG_ 1667 ACN683_0_0_CHECK_SUM "チェックサム
";
CM_ SG_ 957 ACN3BD_4_0_STATE_HT_ACT "HT昇温デバイス作動状態
";
CM_ SG_ 957 ACN3BD_3_3_STATE_HT_CIR "HT回路状態
";
CM_ SG_ 957 ACN3BD_3_0_STATE_HT_CIR_SW "HT回路切替状態
";
CM_ SG_ 957 ACN3BD_2_0_POS_4WV "HT4方弁実開度
";
CM_ SG_ 957 ACN3BD_1_4_ERR_HTDEV "HT昇温デバイス異常状態
";
CM_ SG_ 957 ACN3BD_1_0_MSG_COUNTER "メッセージカウンタ
";
CM_ SG_ 957 ACN3BD_0_0_CHECK_SUM "チェックサム
";
CM_ SG_ 954 ACN3BA_6_0_ACNDEVICE_FIN "空調デバイス終了処理完了フラグ
";
CM_ SG_ 954 ACN3BA_5_3_VOLT_PRT_10WV "LT10方弁電圧保護情報
";
CM_ SG_ 954 ACN3BA_5_1_TEMP_PRT_10WV "LT10方弁温度保護情報
";
CM_ SG_ 954 ACN3BA_4_0_CONT_CHK_10WV "LT10方弁指示確認
";
CM_ SG_ 954 ACN3BA_3_5_V_ERR_10WV "LT10方弁本体異常情報
";
CM_ SG_ 954 ACN3BA_3_3_CR_ERR_10WV "LT10方弁回路異常情報
";
CM_ SG_ 954 ACN3BA_3_1_ERR_CL "チラー吸熱異常状態
";
CM_ SG_ 954 ACN3BA_2_0_POS_10WV "LT10方弁実開度
";
CM_ SG_ 954 ACN3BA_1_6_INI_10WV "LT10方弁イニシャライズ状態
";
CM_ SG_ 954 ACN3BA_1_4_INFO_10WV "LT10方弁情報(LIN)
";
CM_ SG_ 954 ACN3BA_1_0_MSG_COUNTER "メッセージカウンタ
";
CM_ SG_ 954 ACN3BA_0_0_CHECK_SUM "チェックサム
";
CM_ SG_ 1659 ACN67B_6_0_STATE_INW "注排水状態
";
CM_ SG_ 1659 ACN67B_5_2_JUDGE_OIL_SALVAGE "オイル回収必要通知
";
CM_ SG_ 1659 ACN67B_5_0_OIL_SALVAGE_READY "オイル回収実施準備完了フラグ
";
CM_ SG_ 1659 ACN67B_4_3_STATE_ACLOAD "空調負荷状態
";
CM_ SG_ 1659 ACN67B_4_2_REQ_LT_DEF "LTラジ除霜要求
";
CM_ SG_ 1659 ACN67B_4_1_REQ_HT_RAD "HTラジ放熱要求
";
CM_ SG_ 1659 ACN67B_4_0_STATE_BATHP "電池吸熱可否冷媒状態
";
CM_ SG_ 1659 ACN67B_3_4_REQ_ACCYC "空調要求
";
CM_ SG_ 1659 ACN67B_3_3_JUDGE_AMBHP "外気H/P可否状態
";
CM_ SG_ 1659 ACN67B_3_1_RL_LTO "水温センサ信頼性情報(LTラジ出口)
";
CM_ SG_ 1659 ACN67B_2_0_TW_LTO "LTラジ出口水温
";
CM_ SG_ 1659 ACN67B_1_7_JUDGE_LTHP "LT廃熱HP可否状態
";
CM_ SG_ 1659 ACN67B_1_6_HTS_BAT_COMB "熱源不足状態通知(昇温空調併用)
";
CM_ SG_ 1659 ACN67B_1_5_HTS_AC_ALONE "熱源不足状態通知(空調単独)
";
CM_ SG_ 1659 ACN67B_1_4_PERMIT_TL "サーマルループ許可状態
";
CM_ SG_ 1659 ACN67B_1_0_MSG_COUNTER "メッセージカウンタ
";
CM_ SG_ 1659 ACN67B_0_0_CHECK_SUM "チェックサム
";
CM_ SG_ 1656 ACN678_6_0_COMP_W "コンプレッサ仕事量
";
CM_ SG_ 1656 ACN678_4_0_REQ_HC_H "ヒータコア要求放熱量
";
CM_ SG_ 1656 ACN678_2_0_REQ_EVA_H "エバポレータ要求吸熱量
";
CM_ SG_ 1656 ACN678_1_0_MSG_COUNTER "メッセージカウンタ
";
CM_ SG_ 1656 ACN678_0_0_CHECK_SUM "チェックサム
";
CM_ SG_ 949 ACN3B5_7_4_BWP_STATE_FS "バッテリW/P FS状態
";
CM_ SG_ 949 ACN3B5_5_6_HTWP_R "空調(HT)W/P回転数
";
CM_ SG_ 949 ACN3B5_5_4_RL_DE_CLO "水温センサ信頼性情報
(チラー出口_偏差異常)
";
CM_ SG_ 949 ACN3B5_5_1_RL_WC_CLO "水温センサ信頼性情報
(チラー出口_結線異常)
";
CM_ SG_ 949 ACN3B5_4_0_TW_CLO "チラー出口水温
";
CM_ SG_ 949 ACN3B5_3_6_STATE_TW_CL "特殊処理制御実施状態
";
CM_ SG_ 949 ACN3B5_2_0_BWP_R "バッテリW/P回転数
";
CM_ SG_ 949 ACN3B5_1_7_STATE_HTWP "HT W/P作動状態
";
CM_ SG_ 949 ACN3B5_1_4_WC_ERR_BWP "W/P結線異常情報
(バッテリー用W/P)
";
CM_ SG_ 949 ACN3B5_1_0_MSG_COUNTER "メッセージカウンタ
";
CM_ SG_ 949 ACN3B5_0_0_CHECK_SUM "チェックサム
";
CM_ SG_ 1654 ACN676_3_0_HVH_MAX_PW "高電圧水加熱ヒータ 電力上限指示
";
CM_ SG_ 1654 ACN676_2_0_TGT_FANDUTY "目標電動FAN DUTY(空調)
";
CM_ SG_ 1654 ACN676_1_5_REQ_HVH_STB "高電圧水加熱ヒータ STB ON要求
";
CM_ SG_ 1654 ACN676_1_4_REQ_HVH_ON "高電圧水加熱ヒータ ON要求
";
CM_ SG_ 1654 ACN676_1_0_MSG_COUNTER "メッセージカウンタ
";
CM_ SG_ 1654 ACN676_0_0_CHECK_SUM "チェックサム
";
CM_ SG_ 1652 ACN674_7_0_STATE_AC_CONT "A/C制御状態通知
";
CM_ SG_ 1652 ACN674_6_6_REQ_OBD_WARNING "BEVOBD警告灯点灯要求(A/C)
";
CM_ SG_ 1652 ACN674_6_1_REQ_CAUTION_AC "A/C故障による文言表示要求
";
CM_ SG_ 1652 ACN674_6_0_REQ_COMP_STB "インバータSTB ON/OFF要求
(電動コンプレッサ駆動準備信号)
";
CM_ SG_ 1652 ACN674_5_0_ACPRE_AD "冷媒圧力センサデータA/D値
";
CM_ SG_ 1652 ACN674_4_0_COMD_ACCE_ECOMP "電動コンプレッサ指令加速度
";
CM_ SG_ 1652 ACN674_2_0_TGT_ECOMP_R "電動コンプレッサ目標回転数
";
CM_ SG_ 1652 ACN674_1_5_JUDGE_SLOWSTART "スロースタート可否信号
";
CM_ SG_ 1652 ACN674_1_4_JUDGE_COMPWAKE "起動制限可否信号
";
CM_ SG_ 1652 ACN674_1_0_MSG_COUNTER "メッセージカウンタ
";
CM_ SG_ 1652 ACN674_0_0_CHECK_SUM "チェックサム
";
BA_DEF_  "DBCConverterVersion" STRING ;
BA_DEF_  "Manufacturer" STRING ;
BA_DEF_ BU_  "DiagNode" ENUM  "No","Yes";
BA_DEF_ BU_  "ILUsed" ENUM  "No","Yes";
BA_DEF_ BU_  "NodeLayerModules" STRING ;
BA_DEF_ SG_  "Fhi_SignalComment" STRING ;
BA_DEF_ SG_  "GenSigInactiveValue" INT 0 10000;
BA_DEF_ SG_  "GenSigStartValue" FLOAT 0 100000000000;
BA_DEF_ SG_  "GenSigSendType" ENUM  "Cyclic","OnWrite","OnWriteWithRepetition","OnChange","OnChangeWithRepetition","IfActive","IfActiveWithRepetition","NoSigSendType";
BA_DEF_ BO_  "MsgRoutingId" STRING ;
BA_DEF_ BO_  "DiagResponse" ENUM  "No","Yes";
BA_DEF_ BO_  "DiagRequest" ENUM  "No","Yes";
BA_DEF_ BO_  "DiagState" ENUM  "No","Yes";
BA_DEF_ BO_  "GenMsgILSupport" ENUM  "No","Yes";
BA_DEF_ BO_  "GenMsgNrOfRepetition" INT 0 999999;
BA_DEF_ BO_  "GenMsgDelayTime" INT 0 1000;
BA_DEF_ BO_  "GenMsgCycleTimeFast" INT 0 10000;
BA_DEF_ BO_  "GenMsgCycleTime" INT 0 10000;
BA_DEF_ BO_  "GenMsgSendType" ENUM  "Cyclic","NotUsed","NotUsed","NotUsed","NotUsed","Cyclic","NotUsed","IfActive","NoMsgSendType";
BA_DEF_DEF_  "DBCConverterVersion" "2.0";
BA_DEF_DEF_  "Manufacturer" "FHI";
BA_DEF_DEF_  "DiagNode" "No";
BA_DEF_DEF_  "ILUsed" "Yes";
BA_DEF_DEF_  "NodeLayerModules" "CANoeILNLSubaru.dll";
BA_DEF_DEF_  "Fhi_SignalComment" "";
BA_DEF_DEF_  "GenSigInactiveValue" 0;
BA_DEF_DEF_  "GenSigStartValue" 0;
BA_DEF_DEF_  "GenSigSendType" "NoSigSendType";
BA_DEF_DEF_  "MsgRoutingId" "";
BA_DEF_DEF_  "DiagResponse" "No";
BA_DEF_DEF_  "DiagRequest" "No";
BA_DEF_DEF_  "DiagState" "No";
BA_DEF_DEF_  "GenMsgILSupport" "Yes";
BA_DEF_DEF_  "GenMsgNrOfRepetition" 0;
BA_DEF_DEF_  "GenMsgDelayTime" 0;
BA_DEF_DEF_  "GenMsgCycleTimeFast" 0;
BA_DEF_DEF_  "GenMsgCycleTime" 0;
BA_DEF_DEF_  "GenMsgSendType" "Cyclic";
BA_ "DiagNode" BU_ DKY 1;
BA_ "DiagNode" BU_ PSC 1;
BA_ "DiagNode" BU_ MCR 1;
BA_ "DiagNode" BU_ MCL 1;
BA_ "DiagNode" BU_ PRG 1;
BA_ "DiagNode" BU_ AHL 1;
BA_ "DiagNode" BU_ SMT 1;
BA_ "DiagNode" BU_ TPM 1;
BA_ "DiagNode" BU_ ACN 1;
BA_ "DiagNode" BU_ EAM_HUD 1;
BA_ "DiagNode" BU_ DAM 1;
BA_ "DiagNode" BU_ BIU 1;
BA_ "DiagNode" BU_ C_ECU 1;
BA_ "DiagNode" BU_ C_ECU_GW 1;
BA_ "GenMsgSendType" BO_ 1510 8;
BA_ "GenMsgNrOfRepetition" BO_ 1510 1;
BA_ "GenMsgSendType" BO_ 1511 8;
BA_ "GenMsgNrOfRepetition" BO_ 1511 1;
BA_ "GenMsgCycleTime" BO_ 552 50;
BA_ "GenMsgDelayTime" BO_ 552 10;
BA_ "GenMsgNrOfRepetition" BO_ 552 1;
BA_ "MsgRoutingId" BO_ 552 "279 ";
BA_ "GenMsgILSupport" BO_ 552 0;
BA_ "GenMsgCycleTime" BO_ 967 100;
BA_ "GenMsgDelayTime" BO_ 967 50;
BA_ "GenMsgCycleTimeFast" BO_ 967 50;
BA_ "GenMsgNrOfRepetition" BO_ 967 2;
BA_ "MsgRoutingId" BO_ 967 "277 ";
BA_ "GenMsgILSupport" BO_ 967 0;
BA_ "GenMsgCycleTime" BO_ 964 100;
BA_ "GenMsgDelayTime" BO_ 964 50;
BA_ "GenMsgCycleTimeFast" BO_ 964 50;
BA_ "GenMsgNrOfRepetition" BO_ 964 2;
BA_ "MsgRoutingId" BO_ 964 "274 ";
BA_ "GenMsgILSupport" BO_ 964 0;
BA_ "GenMsgCycleTime" BO_ 554 50;
BA_ "MsgRoutingId" BO_ 554 "273 ";
BA_ "GenMsgILSupport" BO_ 554 0;
BA_ "GenMsgCycleTime" BO_ 916 100;
BA_ "GenMsgDelayTime" BO_ 916 10;
BA_ "GenMsgCycleTimeFast" BO_ 916 20;
BA_ "GenMsgNrOfRepetition" BO_ 916 3;
BA_ "MsgRoutingId" BO_ 916 "260 ";
BA_ "GenMsgILSupport" BO_ 916 0;
BA_ "GenMsgCycleTime" BO_ 857 100;
BA_ "GenMsgDelayTime" BO_ 857 10;
BA_ "GenMsgCycleTimeFast" BO_ 857 20;
BA_ "GenMsgNrOfRepetition" BO_ 857 3;
BA_ "MsgRoutingId" BO_ 857 "234 ";
BA_ "GenMsgILSupport" BO_ 857 0;
BA_ "GenMsgCycleTime" BO_ 855 100;
BA_ "GenMsgDelayTime" BO_ 855 10;
BA_ "GenMsgCycleTimeFast" BO_ 855 20;
BA_ "GenMsgNrOfRepetition" BO_ 855 3;
BA_ "MsgRoutingId" BO_ 855 "233 ";
BA_ "GenMsgILSupport" BO_ 855 0;
BA_ "GenMsgCycleTime" BO_ 854 100;
BA_ "GenMsgDelayTime" BO_ 854 10;
BA_ "GenMsgCycleTimeFast" BO_ 854 20;
BA_ "GenMsgNrOfRepetition" BO_ 854 3;
BA_ "MsgRoutingId" BO_ 854 "232 ";
BA_ "GenMsgILSupport" BO_ 854 0;
BA_ "GenMsgCycleTime" BO_ 853 100;
BA_ "GenMsgDelayTime" BO_ 853 10;
BA_ "GenMsgCycleTimeFast" BO_ 853 20;
BA_ "GenMsgNrOfRepetition" BO_ 853 3;
BA_ "MsgRoutingId" BO_ 853 "231 ";
BA_ "GenMsgILSupport" BO_ 853 0;
BA_ "GenMsgCycleTime" BO_ 852 100;
BA_ "GenMsgDelayTime" BO_ 852 10;
BA_ "GenMsgCycleTimeFast" BO_ 852 20;
BA_ "GenMsgNrOfRepetition" BO_ 852 3;
BA_ "MsgRoutingId" BO_ 852 "230 ";
BA_ "GenMsgILSupport" BO_ 852 0;
BA_ "GenMsgCycleTime" BO_ 851 100;
BA_ "MsgRoutingId" BO_ 851 "229 ";
BA_ "GenMsgILSupport" BO_ 851 0;
BA_ "GenMsgCycleTime" BO_ 850 100;
BA_ "GenMsgDelayTime" BO_ 850 10;
BA_ "GenMsgCycleTimeFast" BO_ 850 20;
BA_ "GenMsgNrOfRepetition" BO_ 850 3;
BA_ "MsgRoutingId" BO_ 850 "228 ";
BA_ "GenMsgILSupport" BO_ 850 0;
BA_ "GenMsgCycleTime" BO_ 1537 1000;
BA_ "GenMsgCycleTimeFast" BO_ 1537 10;
BA_ "GenMsgNrOfRepetition" BO_ 1537 5;
BA_ "MsgRoutingId" BO_ 1537 "214 ";
BA_ "GenMsgILSupport" BO_ 1537 0;
BA_ "GenMsgCycleTime" BO_ 267 20;
BA_ "MsgRoutingId" BO_ 267 "211 ";
BA_ "GenMsgILSupport" BO_ 267 0;
BA_ "GenMsgCycleTime" BO_ 116 10;
BA_ "MsgRoutingId" BO_ 116 "209 ";
BA_ "GenMsgILSupport" BO_ 116 0;
BA_ "GenMsgSendType" BO_ 2564481103 8;
BA_ "GenMsgNrOfRepetition" BO_ 2564481103 1;
BA_ "DiagResponse" BO_ 2564481103 1;
BA_ "GenMsgILSupport" BO_ 2564481103 0;
BA_ "MsgRoutingId" BO_ 2564481103 "194 ";
BA_ "GenMsgSendType" BO_ 2564444128 8;
BA_ "GenMsgNrOfRepetition" BO_ 2564444128 1;
BA_ "DiagRequest" BO_ 2564444128 1;
BA_ "GenMsgILSupport" BO_ 2564444128 0;
BA_ "MsgRoutingId" BO_ 2564444128 "193 ";
BA_ "GenMsgSendType" BO_ 2564481205 8;
BA_ "GenMsgNrOfRepetition" BO_ 2564481205 1;
BA_ "DiagResponse" BO_ 2564481205 1;
BA_ "GenMsgILSupport" BO_ 2564481205 0;
BA_ "MsgRoutingId" BO_ 2564481205 "192 ";
BA_ "GenMsgSendType" BO_ 2564470240 8;
BA_ "GenMsgNrOfRepetition" BO_ 2564470240 1;
BA_ "DiagRequest" BO_ 2564470240 1;
BA_ "GenMsgILSupport" BO_ 2564470240 0;
BA_ "MsgRoutingId" BO_ 2564470240 "191 ";
BA_ "GenMsgSendType" BO_ 2564481204 8;
BA_ "GenMsgNrOfRepetition" BO_ 2564481204 1;
BA_ "DiagResponse" BO_ 2564481204 1;
BA_ "GenMsgILSupport" BO_ 2564481204 0;
BA_ "MsgRoutingId" BO_ 2564481204 "190 ";
BA_ "GenMsgSendType" BO_ 2564469984 8;
BA_ "GenMsgNrOfRepetition" BO_ 2564469984 1;
BA_ "DiagRequest" BO_ 2564469984 1;
BA_ "GenMsgILSupport" BO_ 2564469984 0;
BA_ "MsgRoutingId" BO_ 2564469984 "189 ";
BA_ "GenMsgSendType" BO_ 2564481150 8;
BA_ "GenMsgNrOfRepetition" BO_ 2564481150 1;
BA_ "DiagResponse" BO_ 2564481150 1;
BA_ "GenMsgILSupport" BO_ 2564481150 0;
BA_ "MsgRoutingId" BO_ 2564481150 "188 ";
BA_ "GenMsgSendType" BO_ 2564456160 8;
BA_ "GenMsgNrOfRepetition" BO_ 2564456160 1;
BA_ "DiagRequest" BO_ 2564456160 1;
BA_ "GenMsgILSupport" BO_ 2564456160 0;
BA_ "MsgRoutingId" BO_ 2564456160 "187 ";
BA_ "GenMsgSendType" BO_ 1865 8;
BA_ "GenMsgNrOfRepetition" BO_ 1865 1;
BA_ "DiagResponse" BO_ 1865 1;
BA_ "GenMsgILSupport" BO_ 1865 0;
BA_ "MsgRoutingId" BO_ 1865 "184 ";
BA_ "GenMsgSendType" BO_ 1857 8;
BA_ "GenMsgNrOfRepetition" BO_ 1857 1;
BA_ "DiagRequest" BO_ 1857 1;
BA_ "GenMsgILSupport" BO_ 1857 0;
BA_ "MsgRoutingId" BO_ 1857 "183 ";
BA_ "GenMsgSendType" BO_ 1851 8;
BA_ "GenMsgNrOfRepetition" BO_ 1851 1;
BA_ "DiagResponse" BO_ 1851 1;
BA_ "GenMsgILSupport" BO_ 1851 0;
BA_ "MsgRoutingId" BO_ 1851 "180 ";
BA_ "GenMsgSendType" BO_ 1843 8;
BA_ "GenMsgNrOfRepetition" BO_ 1843 1;
BA_ "DiagRequest" BO_ 1843 1;
BA_ "GenMsgILSupport" BO_ 1843 0;
BA_ "MsgRoutingId" BO_ 1843 "179 ";
BA_ "GenMsgSendType" BO_ 2564481214 8;
BA_ "GenMsgNrOfRepetition" BO_ 2564481214 1;
BA_ "DiagResponse" BO_ 2564481214 1;
BA_ "GenMsgILSupport" BO_ 2564481214 0;
BA_ "MsgRoutingId" BO_ 2564481214 "178 ";
BA_ "GenMsgSendType" BO_ 2564472544 8;
BA_ "GenMsgNrOfRepetition" BO_ 2564472544 1;
BA_ "DiagRequest" BO_ 2564472544 1;
BA_ "GenMsgILSupport" BO_ 2564472544 0;
BA_ "MsgRoutingId" BO_ 2564472544 "177 ";
BA_ "GenMsgSendType" BO_ 2564481090 8;
BA_ "GenMsgNrOfRepetition" BO_ 2564481090 1;
BA_ "DiagResponse" BO_ 2564481090 1;
BA_ "GenMsgILSupport" BO_ 2564481090 0;
BA_ "MsgRoutingId" BO_ 2564481090 "162 ";
BA_ "GenMsgSendType" BO_ 2564440800 8;
BA_ "GenMsgNrOfRepetition" BO_ 2564440800 1;
BA_ "DiagRequest" BO_ 2564440800 1;
BA_ "GenMsgILSupport" BO_ 2564440800 0;
BA_ "MsgRoutingId" BO_ 2564440800 "161 ";
BA_ "GenMsgSendType" BO_ 2564468769 8;
BA_ "GenMsgNrOfRepetition" BO_ 2564468769 1;
BA_ "DiagResponse" BO_ 2564468769 1;
BA_ "GenMsgILSupport" BO_ 2564468769 0;
BA_ "MsgRoutingId" BO_ 2564468769 "160 ";
BA_ "GenMsgSendType" BO_ 2564432304 8;
BA_ "GenMsgNrOfRepetition" BO_ 2564432304 1;
BA_ "DiagRequest" BO_ 2564432304 1;
BA_ "GenMsgILSupport" BO_ 2564432304 0;
BA_ "MsgRoutingId" BO_ 2564432304 "159 ";
BA_ "GenMsgSendType" BO_ 2564481142 8;
BA_ "GenMsgNrOfRepetition" BO_ 2564481142 1;
BA_ "DiagResponse" BO_ 2564481142 1;
BA_ "GenMsgILSupport" BO_ 2564481142 0;
BA_ "MsgRoutingId" BO_ 2564481142 "154 ";
BA_ "GenMsgSendType" BO_ 2564454112 8;
BA_ "GenMsgNrOfRepetition" BO_ 2564454112 1;
BA_ "DiagRequest" BO_ 2564454112 1;
BA_ "GenMsgILSupport" BO_ 2564454112 0;
BA_ "MsgRoutingId" BO_ 2564454112 "153 ";
BA_ "GenMsgSendType" BO_ 2564481057 8;
BA_ "GenMsgNrOfRepetition" BO_ 2564481057 1;
BA_ "DiagResponse" BO_ 2564481057 1;
BA_ "GenMsgILSupport" BO_ 2564481057 0;
BA_ "MsgRoutingId" BO_ 2564481057 "152 ";
BA_ "GenMsgSendType" BO_ 2564432352 8;
BA_ "GenMsgNrOfRepetition" BO_ 2564432352 1;
BA_ "DiagRequest" BO_ 2564432352 1;
BA_ "GenMsgILSupport" BO_ 2564432352 0;
BA_ "MsgRoutingId" BO_ 2564432352 "151 ";
BA_ "GenMsgSendType" BO_ 1993 8;
BA_ "GenMsgNrOfRepetition" BO_ 1993 1;
BA_ "DiagResponse" BO_ 1993 1;
BA_ "GenMsgILSupport" BO_ 1993 0;
BA_ "MsgRoutingId" BO_ 1993 "150 ";
BA_ "GenMsgSendType" BO_ 1985 8;
BA_ "GenMsgNrOfRepetition" BO_ 1985 1;
BA_ "DiagRequest" BO_ 1985 1;
BA_ "GenMsgILSupport" BO_ 1985 0;
BA_ "MsgRoutingId" BO_ 1985 "149 ";
BA_ "GenMsgSendType" BO_ 1980 8;
BA_ "GenMsgNrOfRepetition" BO_ 1980 1;
BA_ "DiagResponse" BO_ 1980 1;
BA_ "GenMsgILSupport" BO_ 1980 0;
BA_ "MsgRoutingId" BO_ 1980 "148 ";
BA_ "GenMsgSendType" BO_ 1972 8;
BA_ "GenMsgNrOfRepetition" BO_ 1972 1;
BA_ "DiagRequest" BO_ 1972 1;
BA_ "GenMsgILSupport" BO_ 1972 0;
BA_ "MsgRoutingId" BO_ 1972 "147 ";
BA_ "GenMsgSendType" BO_ 2564502513 8;
BA_ "GenMsgNrOfRepetition" BO_ 2564502513 1;
BA_ "DiagRequest" BO_ 2564502513 1;
BA_ "GenMsgILSupport" BO_ 2564502513 0;
BA_ "MsgRoutingId" BO_ 2564502513 "144 ";
BA_ "GenMsgSendType" BO_ 2564485528 8;
BA_ "GenMsgNrOfRepetition" BO_ 2564485528 1;
BA_ "DiagResponse" BO_ 2564485528 1;
BA_ "GenMsgILSupport" BO_ 2564485528 0;
BA_ "MsgRoutingId" BO_ 2564485528 "143 ";
BA_ "GenMsgSendType" BO_ 2564462833 8;
BA_ "GenMsgNrOfRepetition" BO_ 2564462833 1;
BA_ "DiagRequest" BO_ 2564462833 1;
BA_ "GenMsgILSupport" BO_ 2564462833 0;
BA_ "MsgRoutingId" BO_ 2564462833 "142 ";
BA_ "GenMsgSendType" BO_ 2564481176 8;
BA_ "GenMsgNrOfRepetition" BO_ 2564481176 1;
BA_ "DiagResponse" BO_ 2564481176 1;
BA_ "GenMsgILSupport" BO_ 2564481176 0;
BA_ "MsgRoutingId" BO_ 2564481176 "141 ";
BA_ "GenMsgSendType" BO_ 2564462816 8;
BA_ "GenMsgNrOfRepetition" BO_ 2564462816 1;
BA_ "DiagRequest" BO_ 2564462816 1;
BA_ "GenMsgILSupport" BO_ 2564462816 0;
BA_ "MsgRoutingId" BO_ 2564462816 "140 ";
BA_ "GenMsgSendType" BO_ 1919 8;
BA_ "GenMsgNrOfRepetition" BO_ 1919 1;
BA_ "DiagResponse" BO_ 1919 1;
BA_ "GenMsgILSupport" BO_ 1919 0;
BA_ "MsgRoutingId" BO_ 1919 "139 ";
BA_ "GenMsgSendType" BO_ 1911 8;
BA_ "GenMsgNrOfRepetition" BO_ 1911 1;
BA_ "DiagRequest" BO_ 1911 1;
BA_ "GenMsgILSupport" BO_ 1911 0;
BA_ "MsgRoutingId" BO_ 1911 "138 ";
BA_ "GenMsgSendType" BO_ 1996 8;
BA_ "GenMsgNrOfRepetition" BO_ 1996 1;
BA_ "DiagResponse" BO_ 1996 1;
BA_ "GenMsgILSupport" BO_ 1996 0;
BA_ "MsgRoutingId" BO_ 1996 "137 ";
BA_ "GenMsgSendType" BO_ 1988 8;
BA_ "GenMsgNrOfRepetition" BO_ 1988 1;
BA_ "DiagRequest" BO_ 1988 1;
BA_ "GenMsgILSupport" BO_ 1988 0;
BA_ "MsgRoutingId" BO_ 1988 "136 ";
BA_ "GenMsgSendType" BO_ 2564550625 8;
BA_ "GenMsgNrOfRepetition" BO_ 2564550625 1;
BA_ "DiagState" BO_ 2564550625 1;
BA_ "GenMsgILSupport" BO_ 2564550625 0;
BA_ "GenMsgSendType" BO_ 2564550624 8;
BA_ "GenMsgNrOfRepetition" BO_ 2564550624 1;
BA_ "DiagState" BO_ 2564550624 1;
BA_ "GenMsgILSupport" BO_ 2564550624 0;
BA_ "MsgRoutingId" BO_ 2564550624 "125 ";
BA_ "GenMsgSendType" BO_ 1832 8;
BA_ "GenMsgNrOfRepetition" BO_ 1832 1;
BA_ "DiagState" BO_ 1832 1;
BA_ "GenMsgILSupport" BO_ 1832 0;
BA_ "MsgRoutingId" BO_ 1832 "124 ";
BA_ "GenMsgSendType" BO_ 1880 8;
BA_ "GenMsgNrOfRepetition" BO_ 1880 1;
BA_ "DiagResponse" BO_ 1880 1;
BA_ "GenMsgILSupport" BO_ 1880 0;
BA_ "MsgRoutingId" BO_ 1880 "122 ";
BA_ "GenMsgSendType" BO_ 1872 8;
BA_ "GenMsgNrOfRepetition" BO_ 1872 1;
BA_ "DiagRequest" BO_ 1872 1;
BA_ "GenMsgILSupport" BO_ 1872 0;
BA_ "MsgRoutingId" BO_ 1872 "121 ";
BA_ "GenMsgSendType" BO_ 2564481453 8;
BA_ "GenMsgNrOfRepetition" BO_ 2564481453 1;
BA_ "DiagResponse" BO_ 2564481453 1;
BA_ "GenMsgILSupport" BO_ 2564481453 0;
BA_ "GenMsgSendType" BO_ 2564468193 8;
BA_ "GenMsgNrOfRepetition" BO_ 2564468193 1;
BA_ "DiagRequest" BO_ 2564468193 1;
BA_ "GenMsgILSupport" BO_ 2564468193 0;
BA_ "GenMsgSendType" BO_ 2564481359 8;
BA_ "GenMsgNrOfRepetition" BO_ 2564481359 1;
BA_ "DiagResponse" BO_ 2564481359 1;
BA_ "GenMsgILSupport" BO_ 2564481359 0;
BA_ "GenMsgSendType" BO_ 2564444129 8;
BA_ "GenMsgNrOfRepetition" BO_ 2564444129 1;
BA_ "DiagRequest" BO_ 2564444129 1;
BA_ "GenMsgILSupport" BO_ 2564444129 0;
BA_ "GenMsgSendType" BO_ 2564481406 8;
BA_ "GenMsgNrOfRepetition" BO_ 2564481406 1;
BA_ "DiagResponse" BO_ 2564481406 1;
BA_ "GenMsgILSupport" BO_ 2564481406 0;
BA_ "GenMsgSendType" BO_ 2564456161 8;
BA_ "GenMsgNrOfRepetition" BO_ 2564456161 1;
BA_ "DiagRequest" BO_ 2564456161 1;
BA_ "GenMsgILSupport" BO_ 2564456161 0;
BA_ "GenMsgSendType" BO_ 2564481346 8;
BA_ "GenMsgNrOfRepetition" BO_ 2564481346 1;
BA_ "DiagResponse" BO_ 2564481346 1;
BA_ "GenMsgILSupport" BO_ 2564481346 0;
BA_ "GenMsgSendType" BO_ 2564440801 8;
BA_ "GenMsgNrOfRepetition" BO_ 2564440801 1;
BA_ "DiagRequest" BO_ 2564440801 1;
BA_ "GenMsgILSupport" BO_ 2564440801 0;
BA_ "GenMsgSendType" BO_ 2564481398 8;
BA_ "GenMsgNrOfRepetition" BO_ 2564481398 1;
BA_ "DiagResponse" BO_ 2564481398 1;
BA_ "GenMsgILSupport" BO_ 2564481398 0;
BA_ "GenMsgSendType" BO_ 2564454113 8;
BA_ "GenMsgNrOfRepetition" BO_ 2564454113 1;
BA_ "DiagRequest" BO_ 2564454113 1;
BA_ "GenMsgILSupport" BO_ 2564454113 0;
BA_ "GenMsgSendType" BO_ 2564481313 8;
BA_ "GenMsgNrOfRepetition" BO_ 2564481313 1;
BA_ "DiagResponse" BO_ 2564481313 1;
BA_ "GenMsgILSupport" BO_ 2564481313 0;
BA_ "GenMsgSendType" BO_ 2564432353 8;
BA_ "GenMsgNrOfRepetition" BO_ 2564432353 1;
BA_ "DiagRequest" BO_ 2564432353 1;
BA_ "GenMsgILSupport" BO_ 2564432353 0;
BA_ "GenMsgCycleTime" BO_ 1774 1000;
BA_ "GenMsgCycleTime" BO_ 1773 1000;
BA_ "GenMsgCycleTime" BO_ 1772 1000;
BA_ "GenMsgCycleTime" BO_ 1735 1200;
BA_ "GenMsgDelayTime" BO_ 1735 10;
BA_ "GenMsgCycleTimeFast" BO_ 1735 120;
BA_ "GenMsgNrOfRepetition" BO_ 1735 4;
BA_ "GenMsgCycleTime" BO_ 996 500;
BA_ "GenMsgDelayTime" BO_ 996 10;
BA_ "GenMsgCycleTimeFast" BO_ 996 20;
BA_ "GenMsgNrOfRepetition" BO_ 996 5;
BA_ "GenMsgCycleTime" BO_ 1280 1000;
BA_ "GenMsgCycleTime" BO_ 1633 1000;
BA_ "GenMsgCycleTime" BO_ 1632 500;
BA_ "GenMsgCycleTime" BO_ 1744 1200;
BA_ "GenMsgCycleTimeFast" BO_ 1744 100;
BA_ "GenMsgNrOfRepetition" BO_ 1744 1;
BA_ "GenMsgCycleTime" BO_ 1743 1200;
BA_ "GenMsgCycleTimeFast" BO_ 1743 100;
BA_ "GenMsgNrOfRepetition" BO_ 1743 1;
BA_ "MsgRoutingId" BO_ 1743 "116 ";
BA_ "GenMsgILSupport" BO_ 1743 0;
BA_ "GenMsgDelayTime" BO_ 1630 10;
BA_ "GenMsgSendType" BO_ 1630 8;
BA_ "GenMsgCycleTimeFast" BO_ 1630 20;
BA_ "GenMsgNrOfRepetition" BO_ 1630 1;
BA_ "MsgRoutingId" BO_ 1630 "115 ";
BA_ "GenMsgILSupport" BO_ 1630 0;
BA_ "GenMsgCycleTime" BO_ 1749 1000;
BA_ "GenMsgDelayTime" BO_ 1749 10;
BA_ "GenMsgCycleTimeFast" BO_ 1749 20;
BA_ "GenMsgNrOfRepetition" BO_ 1749 10;
BA_ "GenMsgCycleTime" BO_ 1753 1200;
BA_ "GenMsgDelayTime" BO_ 1753 10;
BA_ "GenMsgNrOfRepetition" BO_ 1753 1;
BA_ "GenMsgCycleTime" BO_ 723 50;
BA_ "GenMsgDelayTime" BO_ 723 10;
BA_ "GenMsgCycleTimeFast" BO_ 723 10;
BA_ "GenMsgNrOfRepetition" BO_ 723 3;
BA_ "GenMsgCycleTime" BO_ 1748 1000;
BA_ "GenMsgDelayTime" BO_ 1748 10;
BA_ "GenMsgNrOfRepetition" BO_ 1748 1;
BA_ "GenMsgCycleTime" BO_ 1757 1200;
BA_ "GenMsgDelayTime" BO_ 1757 10;
BA_ "GenMsgCycleTimeFast" BO_ 1757 120;
BA_ "GenMsgNrOfRepetition" BO_ 1757 3;
BA_ "GenMsgCycleTime" BO_ 1756 1200;
BA_ "GenMsgDelayTime" BO_ 1756 10;
BA_ "GenMsgCycleTimeFast" BO_ 1756 120;
BA_ "GenMsgNrOfRepetition" BO_ 1756 3;
BA_ "GenMsgCycleTime" BO_ 1755 1200;
BA_ "GenMsgDelayTime" BO_ 1755 10;
BA_ "GenMsgCycleTimeFast" BO_ 1755 120;
BA_ "GenMsgNrOfRepetition" BO_ 1755 3;
BA_ "GenMsgCycleTime" BO_ 1754 1200;
BA_ "GenMsgDelayTime" BO_ 1754 10;
BA_ "GenMsgCycleTimeFast" BO_ 1754 120;
BA_ "GenMsgNrOfRepetition" BO_ 1754 3;
BA_ "GenMsgSendType" BO_ 1738 8;
BA_ "GenMsgNrOfRepetition" BO_ 1738 1;
BA_ "GenMsgCycleTime" BO_ 1576 1000;
BA_ "GenMsgNrOfRepetition" BO_ 1576 1;
BA_ "GenMsgSendType" BO_ 1699 8;
BA_ "GenMsgDelayTime" BO_ 1739 10;
BA_ "GenMsgSendType" BO_ 1739 8;
BA_ "GenMsgCycleTimeFast" BO_ 1739 20;
BA_ "GenMsgNrOfRepetition" BO_ 1739 1;
BA_ "MsgRoutingId" BO_ 1739 "114 ";
BA_ "GenMsgILSupport" BO_ 1739 0;
BA_ "GenMsgCycleTime" BO_ 1361 1000;
BA_ "GenMsgCycleTime" BO_ 1677 1200;
BA_ "GenMsgDelayTime" BO_ 1677 10;
BA_ "GenMsgCycleTimeFast" BO_ 1677 200;
BA_ "GenMsgNrOfRepetition" BO_ 1677 5;
BA_ "MsgRoutingId" BO_ 1677 "109 ";
BA_ "GenMsgILSupport" BO_ 1677 0;
BA_ "GenMsgCycleTime" BO_ 1676 1200;
BA_ "GenMsgDelayTime" BO_ 1676 10;
BA_ "GenMsgCycleTimeFast" BO_ 1676 20;
BA_ "MsgRoutingId" BO_ 1676 "108 ";
BA_ "GenMsgILSupport" BO_ 1676 0;
BA_ "GenMsgCycleTime" BO_ 915 100;
BA_ "GenMsgDelayTime" BO_ 915 10;
BA_ "GenMsgCycleTimeFast" BO_ 915 20;
BA_ "GenMsgNrOfRepetition" BO_ 915 2;
BA_ "MsgRoutingId" BO_ 915 "106 ";
BA_ "GenMsgILSupport" BO_ 915 0;
BA_ "GenMsgCycleTime" BO_ 912 100;
BA_ "GenMsgDelayTime" BO_ 912 10;
BA_ "GenMsgCycleTimeFast" BO_ 912 50;
BA_ "GenMsgNrOfRepetition" BO_ 912 4;
BA_ "MsgRoutingId" BO_ 912 "105 ";
BA_ "GenMsgILSupport" BO_ 912 0;
BA_ "GenMsgCycleTime" BO_ 937 100;
BA_ "GenMsgDelayTime" BO_ 937 10;
BA_ "GenMsgCycleTimeFast" BO_ 937 50;
BA_ "GenMsgNrOfRepetition" BO_ 937 4;
BA_ "MsgRoutingId" BO_ 937 "102 ";
BA_ "GenMsgILSupport" BO_ 937 0;
BA_ "GenMsgCycleTime" BO_ 933 100;
BA_ "GenMsgDelayTime" BO_ 933 10;
BA_ "GenMsgCycleTimeFast" BO_ 933 20;
BA_ "GenMsgNrOfRepetition" BO_ 933 2;
BA_ "MsgRoutingId" BO_ 933 "101 ";
BA_ "GenMsgILSupport" BO_ 933 0;
BA_ "GenMsgCycleTime" BO_ 1614 1200;
BA_ "GenMsgDelayTime" BO_ 1614 10;
BA_ "GenMsgCycleTimeFast" BO_ 1614 50;
BA_ "MsgRoutingId" BO_ 1614 "96 ";
BA_ "GenMsgCycleTime" BO_ 1285 1000;
BA_ "GenMsgCycleTime" BO_ 1658 1000;
BA_ "MsgRoutingId" BO_ 1658 "95 ";
BA_ "GenMsgCycleTime" BO_ 1657 1000;
BA_ "MsgRoutingId" BO_ 1657 "94 ";
BA_ "GenMsgCycleTime" BO_ 827 120;
BA_ "GenMsgDelayTime" BO_ 827 10;
BA_ "GenMsgCycleTimeFast" BO_ 827 120;
BA_ "GenMsgNrOfRepetition" BO_ 827 50;
BA_ "MsgRoutingId" BO_ 827 "93 ";
BA_ "GenMsgILSupport" BO_ 827 0;
BA_ "GenMsgCycleTime" BO_ 826 120;
BA_ "GenMsgDelayTime" BO_ 826 10;
BA_ "GenMsgCycleTimeFast" BO_ 826 120;
BA_ "GenMsgNrOfRepetition" BO_ 826 50;
BA_ "MsgRoutingId" BO_ 826 "92 ";
BA_ "GenMsgILSupport" BO_ 826 0;
BA_ "GenMsgCycleTime" BO_ 961 120;
BA_ "GenMsgCycleTimeFast" BO_ 961 50;
BA_ "GenMsgNrOfRepetition" BO_ 961 3;
BA_ "MsgRoutingId" BO_ 961 "91 ";
BA_ "GenMsgILSupport" BO_ 961 0;
BA_ "GenMsgCycleTime" BO_ 1651 1200;
BA_ "GenMsgDelayTime" BO_ 1651 10;
BA_ "GenMsgCycleTimeFast" BO_ 1651 20;
BA_ "GenMsgNrOfRepetition" BO_ 1651 3;
BA_ "MsgRoutingId" BO_ 1651 "89 ";
BA_ "GenMsgCycleTime" BO_ 1650 1200;
BA_ "GenMsgDelayTime" BO_ 1650 10;
BA_ "GenMsgCycleTimeFast" BO_ 1650 20;
BA_ "GenMsgNrOfRepetition" BO_ 1650 3;
BA_ "MsgRoutingId" BO_ 1650 "88 ";
BA_ "GenMsgCycleTime" BO_ 722 30;
BA_ "MsgRoutingId" BO_ 722 "87 ";
BA_ "GenMsgCycleTime" BO_ 1373 1000;
BA_ "GenMsgCycleTime" BO_ 1667 1200;
BA_ "GenMsgDelayTime" BO_ 1667 10;
BA_ "GenMsgCycleTimeFast" BO_ 1667 20;
BA_ "GenMsgNrOfRepetition" BO_ 1667 3;
BA_ "MsgRoutingId" BO_ 1667 "86 ";
BA_ "GenMsgCycleTime" BO_ 957 100;
BA_ "GenMsgDelayTime" BO_ 957 10;
BA_ "GenMsgNrOfRepetition" BO_ 957 1;
BA_ "MsgRoutingId" BO_ 957 "85 ";
BA_ "GenMsgCycleTime" BO_ 954 100;
BA_ "GenMsgDelayTime" BO_ 954 10;
BA_ "GenMsgNrOfRepetition" BO_ 954 1;
BA_ "MsgRoutingId" BO_ 954 "84 ";
BA_ "GenMsgCycleTime" BO_ 1659 1000;
BA_ "GenMsgDelayTime" BO_ 1659 10;
BA_ "GenMsgCycleTimeFast" BO_ 1659 20;
BA_ "GenMsgNrOfRepetition" BO_ 1659 3;
BA_ "MsgRoutingId" BO_ 1659 "83 ";
BA_ "GenMsgCycleTime" BO_ 1656 1000;
BA_ "MsgRoutingId" BO_ 1656 "82 ";
BA_ "GenMsgCycleTime" BO_ 949 100;
BA_ "GenMsgDelayTime" BO_ 949 10;
BA_ "GenMsgNrOfRepetition" BO_ 949 1;
BA_ "MsgRoutingId" BO_ 949 "81 ";
BA_ "GenMsgCycleTime" BO_ 1654 1000;
BA_ "GenMsgDelayTime" BO_ 1654 10;
BA_ "GenMsgCycleTimeFast" BO_ 1654 20;
BA_ "GenMsgNrOfRepetition" BO_ 1654 3;
BA_ "MsgRoutingId" BO_ 1654 "80 ";
BA_ "GenMsgCycleTime" BO_ 1652 1000;
BA_ "GenMsgDelayTime" BO_ 1652 10;
BA_ "GenMsgCycleTimeFast" BO_ 1652 20;
BA_ "GenMsgNrOfRepetition" BO_ 1652 3;
BA_ "MsgRoutingId" BO_ 1652 "79 ";
BA_ "GenSigSendType" SG_ 1511 EAM5E7_7_0_DATA 2;
BA_ "GenSigStartValue" SG_ 552 RDR228_6_5_BLOCKAGE_STS 5;
BA_ "GenSigSendType" SG_ 552 RDR228_4_3_WARN_DOW_2ST_R 3;
BA_ "GenSigSendType" SG_ 552 RDR228_4_4_WARN_DOW_2ST_L 3;
BA_ "GenSigStartValue" SG_ 552 RDR228_3_0_WARN_BSD_LCA_R_2ND 1;
BA_ "Fhi_SignalComment" SG_ 552 RDR228_2_6_ON_OFF_RDRSYS "SW情報：ﾗｽﾄﾒﾓﾘ

";
BA_ "GenSigStartValue" SG_ 552 RDR228_1_4_BATT_OFF_CAUSE 1;
BA_ "GenSigStartValue" SG_ 857 THM359_2_0_HVBINLTEMP 130;
BA_ "GenSigStartValue" SG_ 855 THM357_7_0_ACNINVTEMP 60;
BA_ "GenSigStartValue" SG_ 855 THM357_5_0_NVLMT 1;
BA_ "GenSigStartValue" SG_ 853 THM355_4_0_HWPINSTDUTY 819;
BA_ "GenSigStartValue" SG_ 851 THM353_4_0_LTCCLGTGTCLTP 511;
BA_ "GenSigStartValue" SG_ 850 THM352_3_0_BWPINSTDUTY 819;
BA_ "GenSigStartValue" SG_ 116 BEV074_3_0_RANGE_POS 6;
BA_ "GenSigSendType" SG_ 2564481103 PSM18DAE04F_DIAG_DATA 2;
BA_ "GenSigSendType" SG_ 2564444128 DNT18DA4FE0_DIAG_DATA 2;
BA_ "GenSigSendType" SG_ 2564481205 MEP18DAE0B5_DIAG_DATA 2;
BA_ "GenSigSendType" SG_ 2564470240 DNT18DAB5E0_DIAG_DATA 2;
BA_ "GenSigSendType" SG_ 2564481204 MED18DAE0B4_DIAG_DATA 2;
BA_ "GenSigSendType" SG_ 2564469984 DNT18DAB4E0_DIAG_DATA 2;
BA_ "GenSigSendType" SG_ 2564481150 PRG18DAE07E_DIAG_DATA 2;
BA_ "GenSigSendType" SG_ 2564456160 DNT18DA7EE0_DIAG_DATA 2;
BA_ "GenSigSendType" SG_ 1865 DAM749_7_0_DIAG_DATA 2;
BA_ "GenSigSendType" SG_ 1865 DAM749_2_0_DIAG_N_PCI_OR_DATA 2;
BA_ "GenSigSendType" SG_ 1865 DAM749_1_0_DIAG_N_PCI_OR_DATA 2;
BA_ "GenSigSendType" SG_ 1865 DAM749_0_0_DIAG_N_PCI 2;
BA_ "GenSigSendType" SG_ 1857 DNT741_7_0_DIAG_DATA 2;
BA_ "GenSigSendType" SG_ 1857 DNT741_2_0_DIAG_N_PCI_OR_DATA 2;
BA_ "GenSigSendType" SG_ 1857 DNT741_1_0_DIAG_N_PCI_OR_DATA 2;
BA_ "GenSigSendType" SG_ 1857 DNT741_0_0_DIAG_N_PCI 2;
BA_ "GenSigSendType" SG_ 1851 EAM73B_7_0_DIAG_DATA 2;
BA_ "GenSigSendType" SG_ 1851 EAM73B_2_0_DIAG_N_PCI_OR_DATA 2;
BA_ "GenSigSendType" SG_ 1851 EAM73B_1_0_DIAG_N_PCI_OR_DATA 2;
BA_ "GenSigSendType" SG_ 1851 EAM73B_0_0_DIAG_N_PCI 2;
BA_ "GenSigSendType" SG_ 1843 DNT733_7_0_DIAG_DATA 2;
BA_ "GenSigSendType" SG_ 1843 DNT733_2_0_DIAG_N_PCI_OR_DATA 2;
BA_ "GenSigSendType" SG_ 1843 DNT733_1_0_DIAG_N_PCI_OR_DATA 2;
BA_ "GenSigSendType" SG_ 1843 DNT733_0_0_DIAG_N_PCI 2;
BA_ "GenSigSendType" SG_ 2564481214 RKE18DAE0BE_DIAG_DATA 2;
BA_ "GenSigSendType" SG_ 2564472544 DNT18DABEE0_DIAG_DATA 2;
BA_ "GenSigSendType" SG_ 2564481090 AHL18DAE042_DIAG_DATA 2;
BA_ "GenSigSendType" SG_ 2564440800 DNT18DA42E0_DIAG_DATA 2;
BA_ "GenSigSendType" SG_ 2564468769 BIU18DAB021_DIAG_DATA 2;
BA_ "GenSigSendType" SG_ 2564432304 AVN18DA21B0_DIAG_DATA 2;
BA_ "GenSigSendType" SG_ 2564481142 TPM18DAE076_DIAG_DATA 2;
BA_ "GenSigSendType" SG_ 2564454112 DNT18DA76E0_DIAG_DATA 2;
BA_ "GenSigSendType" SG_ 2564481057 BIU18DAE021_DIAG_DATA 2;
BA_ "GenSigSendType" SG_ 2564432352 DNT18DA21E0_DIAG_DATA 2;
BA_ "GenSigSendType" SG_ 1993 PMN7C9_7_0_DIAG_DATA 2;
BA_ "GenSigSendType" SG_ 1993 PMN7C9_2_0_DIAG_N_PCI_OR_DATA 2;
BA_ "GenSigSendType" SG_ 1993 PMN7C9_1_0_DIAG_N_PCI_OR_DATA 2;
BA_ "GenSigSendType" SG_ 1993 PMN7C9_0_0_DIAG_N_PCI 2;
BA_ "GenSigSendType" SG_ 1985 DNT7C1_7_0_DIAG_DATA 2;
BA_ "GenSigSendType" SG_ 1985 DNT7C1_2_0_DIAG_N_PCI_OR_DATA 2;
BA_ "GenSigSendType" SG_ 1985 DNT7C1_1_0_DIAG_N_PCI_OR_DATA 2;
BA_ "GenSigSendType" SG_ 1985 DNT7C1_0_0_DIAG_N_PCI 2;
BA_ "GenSigSendType" SG_ 1980 SMT7BC_7_0_DIAG_DATA 2;
BA_ "GenSigSendType" SG_ 1980 SMT7BC_2_0_DIAG_N_PCI_OR_DATA 2;
BA_ "GenSigSendType" SG_ 1980 SMT7BC_1_0_DIAG_N_PCI_OR_DATA 2;
BA_ "GenSigSendType" SG_ 1980 SMT7BC_0_0_DIAG_N_PCI 2;
BA_ "GenSigSendType" SG_ 1972 DNT7B4_7_0_DIAG_DATA 2;
BA_ "GenSigSendType" SG_ 1972 DNT7B4_2_0_DIAG_N_PCI_OR_DATA 2;
BA_ "GenSigSendType" SG_ 1972 DNT7B4_1_0_DIAG_N_PCI_OR_DATA 2;
BA_ "GenSigSendType" SG_ 1972 DNT7B4_0_0_DIAG_N_PCI 2;
BA_ "GenSigSendType" SG_ 2564502513 DNT18DB33F1_DIAG_DATA 2;
BA_ "GenSigSendType" SG_ 2564485528 ACN18DAF198_DIAG_DATA 2;
BA_ "GenSigSendType" SG_ 2564462833 DNT18DA98F1_DIAG_DATA 2;
BA_ "GenSigSendType" SG_ 2564481176 ACN18DAE098_DIAG_DATA 2;
BA_ "GenSigSendType" SG_ 2564462816 DNT18DA98E0_DIAG_DATA 2;
BA_ "GenSigSendType" SG_ 1919 ACN77F_7_0_DIAG_DATA 2;
BA_ "GenSigSendType" SG_ 1919 ACN77F_2_0_DIAG_N_PCI_OR_DATA 2;
BA_ "GenSigSendType" SG_ 1919 ACN77F_1_0_DIAG_N_PCI_OR_DATA 2;
BA_ "GenSigSendType" SG_ 1919 ACN77F_0_0_DIAG_N_PCI 2;
BA_ "GenSigSendType" SG_ 1911 DNT777_7_0_DIAG_DATA 2;
BA_ "GenSigSendType" SG_ 1911 DNT777_2_0_DIAG_N_PCI_OR_DATA 2;
BA_ "GenSigSendType" SG_ 1911 DNT777_1_0_DIAG_N_PCI_OR_DATA 2;
BA_ "GenSigSendType" SG_ 1911 DNT777_0_0_DIAG_N_PCI 2;
BA_ "GenSigSendType" SG_ 1996 ACN7CC_7_0_DIAG_DATA 2;
BA_ "GenSigSendType" SG_ 1996 ACN7CC_2_0_DIAG_N_PCI_OR_DATA 2;
BA_ "GenSigSendType" SG_ 1996 ACN7CC_1_0_DIAG_N_PCI_OR_DATA 2;
BA_ "GenSigSendType" SG_ 1996 ACN7CC_0_0_DIAG_N_PCI 2;
BA_ "GenSigSendType" SG_ 1988 DNT7C4_7_0_DIAG_DATA 2;
BA_ "GenSigSendType" SG_ 1988 DNT7C4_2_0_DIAG_N_PCI_OR_DATA 2;
BA_ "GenSigSendType" SG_ 1988 DNT7C4_1_0_DIAG_N_PCI_OR_DATA 2;
BA_ "GenSigSendType" SG_ 1988 DNT7C4_0_0_DIAG_N_PCI 2;
BA_ "GenSigSendType" SG_ 2564550625 CECU18DBEFE1_DIAG_DATA 2;
BA_ "GenSigSendType" SG_ 2564550624 DNT18DBEFE0_DIAG_DATA 2;
BA_ "GenSigSendType" SG_ 1832 DNT728_7_0_DIAG_DATA 2;
BA_ "GenSigSendType" SG_ 1832 DNT728_2_0_DIAG_N_PCI_OR_DATA 2;
BA_ "GenSigSendType" SG_ 1832 DNT728_1_0_DIAG_N_PCI_OR_DATA 2;
BA_ "GenSigSendType" SG_ 1832 DNT728_0_0_DIAG_N_PCI 2;
BA_ "GenSigSendType" SG_ 1880 RBB758_7_0_DIAG_DATA 2;
BA_ "GenSigSendType" SG_ 1880 RBB758_3_0_DIAG_N_PCI_OR_DATA 2;
BA_ "GenSigSendType" SG_ 1880 RBB758_2_0_DIAG_N_PCI_OR_DATA 2;
BA_ "GenSigSendType" SG_ 1880 RBB758_1_0_DIAG_N_PCI 2;
BA_ "GenSigSendType" SG_ 1880 RBB758_0_0_DIAG_N_TA 2;
BA_ "GenSigSendType" SG_ 1872 DNT750_7_0_DIAG_DATA 2;
BA_ "GenSigSendType" SG_ 1872 DNT750_3_0_DIAG_N_PCI_OR_DATA 2;
BA_ "GenSigSendType" SG_ 1872 DNT750_2_0_DIAG_N_PCI_OR_DATA 2;
BA_ "GenSigSendType" SG_ 1872 DNT750_1_0_DIAG_N_PCI 2;
BA_ "GenSigSendType" SG_ 1872 DNT750_0_0_DIAG_N_TA 2;
BA_ "GenSigSendType" SG_ 2564481453 EAM18DAE1AD_DIAG_DATA 2;
BA_ "GenSigSendType" SG_ 2564468193 CECU18DAADE1_DIAG_DATA 2;
BA_ "GenSigSendType" SG_ 2564481359 PSM18DAE14F_DIAG_DATA 2;
BA_ "GenSigSendType" SG_ 2564444129 CECU18DA4FE1_DIAG_DATA 2;
BA_ "GenSigSendType" SG_ 2564481406 PRG18DAE17E_DIAG_DATA 2;
BA_ "GenSigSendType" SG_ 2564456161 CECU18DA7EE1_DIAG_DATA 2;
BA_ "GenSigSendType" SG_ 2564481346 AHL18DAE142_DIAG_DATA 2;
BA_ "GenSigSendType" SG_ 2564440801 CECU18DA42E1_DIAG_DATA 2;
BA_ "GenSigSendType" SG_ 2564481398 TPM18DAE176_DIAG_DATA 2;
BA_ "GenSigSendType" SG_ 2564454113 CECU18DA76E1_DIAG_DATA 2;
BA_ "GenSigSendType" SG_ 2564481313 BIU18DAE121_DIAG_DATA 2;
BA_ "GenSigSendType" SG_ 2564432353 CECU18DA21E1_DIAG_DATA 2;
BA_ "GenSigStartValue" SG_ 1735 CECU6C7_4_0_Dr_TEMP_SETTING 63;
BA_ "GenSigStartValue" SG_ 996 CECU3E4_6_0_CHARGE_LEVEL_ENG_RUN 3;
BA_ "GenSigStartValue" SG_ 996 CECU3E4_6_4_CHARGE_LEVEL_IGN_ON 3;
BA_ "GenSigStartValue" SG_ 1632 CGW660_1_0_SUB_ID 65535;
BA_ "GenSigSendType" SG_ 1630 DCM65E_2_0_DATA2 4;
BA_ "GenSigSendType" SG_ 1630 DCM65E_1_4_DATA1 4;
BA_ "GenSigSendType" SG_ 1753 CECU6D9_2_0_RCC_DOOR_LOCK_REQ 3;
BA_ "GenSigSendType" SG_ 1753 CECU6D9_2_1_RCC_KEY_SEARCH_REQ 3;
BA_ "GenSigSendType" SG_ 1753 CECU6D9_2_2_RCC_BWAM_SETTING 3;
BA_ "GenSigSendType" SG_ 1753 CECU6D9_1_4_RCC_FLG 3;
BA_ "GenSigSendType" SG_ 1753 CECU6D9_0_0_CHECK_SUM 3;
BA_ "GenSigSendType" SG_ 1748 CECU6D4_4_0_TARGET_POS_PRG 3;
BA_ "GenSigSendType" SG_ 1748 CECU6D4_2_0_REQ_PRG_STOP 3;
BA_ "GenSigSendType" SG_ 1748 CECU6D4_2_1_REQ_PRG_ACT 3;
BA_ "GenSigStartValue" SG_ 1757 CECU6DD_2_0_VEHICLE_RUN 3;
BA_ "GenSigStartValue" SG_ 1756 CECU6DC_6_0_TARGET_POS_MIR_RMR 16383;
BA_ "GenSigStartValue" SG_ 1756 CECU6DC_4_0_TARGET_POS_MIR_LMR 16383;
BA_ "GenSigSendType" SG_ 1738 CECU6CA_5_2_REQ_DEV 2;
BA_ "GenSigSendType" SG_ 1738 CECU6CA_5_6_REQ_OWCQ 2;
BA_ "GenSigSendType" SG_ 1738 CECU6CA_4_0_RGMDDK1_CECU 2;
BA_ "GenSigSendType" SG_ 1738 CECU6CA_2_0_ID_D_DEL 2;
BA_ "GenSigSendType" SG_ 1738 CECU6CA_0_0_RQRGDK 2;
BA_ "GenSigStartValue" SG_ 1576 CECU628_3_4_CAN_MCC 4095;
BA_ "GenSigSendType" SG_ 1576 CECU628_1_0_MSG_COUNTER 1;
BA_ "GenSigSendType" SG_ 1576 CECU628_0_0_CHECKSUM 3;
BA_ "GenSigSendType" SG_ 1739 DCM6CB_5_0_DKY_SLOT_ID 4;
BA_ "GenSigSendType" SG_ 1739 DCM6CB_4_0_DKY_COM_REQ 4;
BA_ "GenSigSendType" SG_ 1739 DCM6CB_3_5_PNC_SW_REQ_SRV 4;
BA_ "GenSigSendType" SG_ 1739 DCM6CB_2_0_SHUTDOWN_REQ 4;
BA_ "GenSigSendType" SG_ 1739 DCM6CB_2_3_IGB_OFF_REQUEST 4;
BA_ "GenSigSendType" SG_ 1739 DCM6CB_2_4_IGB_ON_REQUEST 4;
BA_ "GenSigSendType" SG_ 1739 DCM6CB_2_5_REARGATE_UNLOCK_REQ 4;
BA_ "GenSigSendType" SG_ 1739 DCM6CB_2_6_DOOR_UNLOCK_REQ 4;
BA_ "GenSigSendType" SG_ 1739 DCM6CB_2_7_DOOR_LOCK_REQUEST 4;
BA_ "GenSigSendType" SG_ 1739 DCM6CB_1_4_REQ_SVR_HAZARD_ON 4;
BA_ "GenSigSendType" SG_ 1739 DCM6CB_1_5_HORNHZRD_DEACT_REQ 4;
BA_ "GenSigSendType" SG_ 1739 DCM6CB_1_6_HAZARD_ACT_REQ 4;
BA_ "GenSigSendType" SG_ 1739 DCM6CB_1_7_HORNHAZARD_ACT_REQ 4;
BA_ "GenSigStartValue" SG_ 1677 MET68D_5_0_TEMP_FOR_PPA 8191;
BA_ "Fhi_SignalComment" SG_ 1677 MET68D_2_0_ODO "000000h～98967Fh：正常

989680h～FFFFFEh：未使用

FFFFFFh：異常

";
BA_ "GenSigStartValue" SG_ 1676 MET68C_2_0_CRUISING_RADIUS 254;
BA_ "GenSigStartValue" SG_ 915 MET393_6_0_R_DIFF_TEMP 253;
BA_ "Fhi_SignalComment" SG_ 915 MET393_6_0_R_DIFF_TEMP "IGN-ON初回送信時はFEhを送信する。

";
BA_ "GenSigStartValue" SG_ 915 MET393_4_0_FUEL_LEVEL_RESIST 1022;
BA_ "Fhi_SignalComment" SG_ 915 MET393_3_5_SI_DRIVE_SW "IGN　ON時の初期値は各SIドライブとXモードの組み合わせにより異なる。

";
BA_ "GenSigStartValue" SG_ 915 MET393_2_0_OUTTEMP_FOR_DIAG 8191;
BA_ "Fhi_SignalComment" SG_ 912 MET390_6_0_SEATBELT_DRVR "IGN-OFF中は0送信

";
BA_ "Fhi_SignalComment" SG_ 912 MET390_6_1_SEATBELT_PASS "IGN-OFF中は0送信

";
BA_ "GenSigStartValue" SG_ 912 MET390_4_0_OUTTEMP_FOR_IND 254;
BA_ "Fhi_SignalComment" SG_ 912 MET390_4_0_OUTTEMP_FOR_IND "IGN-OFF中は初期値：FEh送信

";
BA_ "Fhi_SignalComment" SG_ 912 MET390_2_0_VEHICLE_SERIES "GW:ID390-B2b2~b0→ID2BE-B5b2~b0

";
BA_ "Fhi_SignalComment" SG_ 912 MET390_2_3_DESTINATION "GW:ID390-B2b6~b3→ID2BE-B5b6~b3

";
BA_ "GenSigStartValue" SG_ 933 MET3A5_7_0_INSTCNSP_VAL 1022;
BA_ "GenSigStartValue" SG_ 933 MET3A5_5_0_AVEN_TRIPB_VAL 1022;
BA_ "GenSigStartValue" SG_ 933 MET3A5_3_0_AVEN_TRIPA_VAL 1022;
BA_ "GenSigSendType" SG_ 1658 TPM67A_6_1_TIRE_COLOR_RR 3;
BA_ "GenSigSendType" SG_ 1658 TPM67A_6_5_TIRE_COLOR_RL 3;
BA_ "GenSigSendType" SG_ 1658 TPM67A_6_7_TIRE_PRESSURE_RL 3;
BA_ "GenSigSendType" SG_ 1658 TPM67A_5_0_TIRE_PRESSURE_RR 3;
BA_ "GenSigSendType" SG_ 1658 TPM67A_3_1_TIRE_COLOR_FL 3;
BA_ "GenSigSendType" SG_ 1658 TPM67A_3_5_TIRE_COLOR_FR 3;
BA_ "GenSigSendType" SG_ 1658 TPM67A_3_7_TIRE_PRESSURE_FR 3;
BA_ "GenSigSendType" SG_ 1658 TPM67A_2_0_TIRE_PRESSURE_FL 3;
BA_ "GenSigSendType" SG_ 1658 TPM67A_1_5_UNIT_IND_PRESSURE 3;
BA_ "GenSigSendType" SG_ 1658 TPM67A_1_7_IND_PRESSURE 3;
BA_ "GenSigSendType" SG_ 1657 TPM679_3_0_STATE_TPMS 3;
BA_ "Fhi_SignalComment" SG_ 1657 TPM679_3_2_DEFINED_STATE_TPMS "※閾値設定スイッチがタッチパネルの車は、送信値を0固定とする。

";
BA_ "GenSigSendType" SG_ 1657 TPM679_3_2_DEFINED_STATE_TPMS 3;
BA_ "GenSigSendType" SG_ 1657 TPM679_2_0_WARN_TPMS 3;
BA_ "GenSigSendType" SG_ 1657 TPM679_2_3_INTERRUPT 3;
BA_ "GenSigStartValue" SG_ 827 ABG33B_4_0_PASSENGER_BELT_INFO 2;
BA_ "GenSigStartValue" SG_ 827 ABG33B_4_2_PASSENGER_DETECT_INFO 4;
BA_ "GenSigStartValue" SG_ 827 ABG33B_2_0_IND_WARN_PPA 3;
BA_ "GenSigStartValue" SG_ 826 ABG33A_3_0_BELT_WRNING_PASS 2;
BA_ "GenSigStartValue" SG_ 826 ABG33A_3_4_OCCUPATION_PASS 2;
BA_ "GenSigStartValue" SG_ 826 ABG33A_2_0_IND_WARN_ABG 3;
BA_ "GenSigStartValue" SG_ 961 DMS3C1_6_2_PERMIT_AVN_FLAG 1;
BA_ "GenSigStartValue" SG_ 961 DMS3C1_6_7_NOT_DETECTED_STATUS 1;
BA_ "GenSigStartValue" SG_ 961 DMS3C1_4_0_DMS_IND_REQ_FLAG 7;
BA_ "GenSigStartValue" SG_ 961 DMS3C1_4_3_DMS_RECOG_STATUS 1;
BA_ "GenSigSendType" SG_ 957 ACN3BD_3_3_STATE_HT_CIR 3;
BA_ "GenSigSendType" SG_ 957 ACN3BD_3_0_STATE_HT_CIR_SW 3;
BA_ "GenSigSendType" SG_ 957 ACN3BD_1_4_ERR_HTDEV 3;
BA_ "GenSigSendType" SG_ 954 ACN3BA_6_0_ACNDEVICE_FIN 3;
BA_ "GenSigSendType" SG_ 954 ACN3BA_5_3_VOLT_PRT_10WV 3;
BA_ "GenSigSendType" SG_ 954 ACN3BA_5_1_TEMP_PRT_10WV 3;
BA_ "GenSigSendType" SG_ 949 ACN3B5_7_4_BWP_STATE_FS 3;
BA_ "GenSigSendType" SG_ 949 ACN3B5_1_7_STATE_HTWP 3;
VAL_ 552 RDR228_7_0_EYE_TIMEOUT_ERROR_FLG 1 "EYE Timeout or Error detect" 0 "Normal" ;
VAL_ 552 RDR228_7_1_BLOCKAGE_FORMING_2 1 "Blocakge2" 0 "Normal" ;
VAL_ 552 RDR228_7_2_WARN_LCA_R_1ST 1 "ON" 0 "OFF" ;
VAL_ 552 RDR228_7_3_WARN_LCA_L_1ST 1 "ON" 0 "OFF" ;
VAL_ 552 RDR228_7_4_WARN_LCA_R_2ND 1 "ON" 0 "OFF" ;
VAL_ 552 RDR228_7_5_WARN_LCA_L_2ND 1 "ON" 0 "OFF" ;
VAL_ 552 RDR228_7_6_WARN_RCTA_R 1 "ON" 0 "OFF" ;
VAL_ 552 RDR228_7_7_WARN_RCTA_L 1 "ON" 0 "OFF" ;
VAL_ 552 RDR228_6_0_WARN_BSD_R_1ST 1 "ON" 0 "OFF" ;
VAL_ 552 RDR228_6_1_WARN_BSD_L_1ST 1 "ON" 0 "OFF" ;
VAL_ 552 RDR228_6_2_WARN_BSD_R_2ND 1 "ON" 0 "OFF" ;
VAL_ 552 RDR228_6_3_WARN_BSD_L_2ND 1 "ON" 0 "OFF" ;
VAL_ 552 RDR228_6_5_BLOCKAGE_STS 5 "INVALID" 4 "BLIND" 3 "HIGH" 2 "MID" 1 "LOW" 0 "NONE" ;
VAL_ 552 RDR228_5_0_BSD_R_E 1 "ON" 0 "OFF" ;
VAL_ 552 RDR228_5_1_BSD_L_E 1 "ON" 0 "OFF" ;
VAL_ 552 RDR228_5_2_LCA_R_E 1 "ON" 0 "OFF" ;
VAL_ 552 RDR228_5_3_LCA_L_E 1 "ON" 0 "OFF" ;
VAL_ 552 RDR228_5_4_BSD_R_A 1 "ON" 0 "OFF" ;
VAL_ 552 RDR228_5_5_BSD_L_A 1 "ON" 0 "OFF" ;
VAL_ 552 RDR228_5_6_LCA_R_A 1 "ON" 0 "OFF" ;
VAL_ 552 RDR228_5_7_LCA_L_A 1 "ON" 0 "OFF" ;
VAL_ 552 RDR228_4_0_DOW_ACTIVELAMP 1 "ON" 0 "OFF" ;
VAL_ 552 RDR228_4_1_WARN_DOW_1ST_R 1 "ON" 0 "OFF" ;
VAL_ 552 RDR228_4_2_WARN_DOW_1ST_L 1 "ON" 0 "OFF" ;
VAL_ 552 RDR228_4_3_WARN_DOW_2ST_R 1 "ON" 0 "OFF" ;
VAL_ 552 RDR228_4_4_WARN_DOW_2ST_L 1 "ON" 0 "OFF" ;
VAL_ 552 RDR228_4_6_CSTM_STS_BSD_LCA_2ND 1 "ON" 0 "OFF" ;
VAL_ 552 RDR228_4_7_CSTM_STS_RCTA 1 "ON" 0 "OFF" ;
VAL_ 552 RDR228_3_0_WARN_BSD_LCA_R_2ND 1 "ON" 0 "OFF" ;
VAL_ 552 RDR228_3_1_WARN_BSD_LCA_L_2ND 1 "ON" 0 "OFF" ;
VAL_ 552 RDR228_3_2_CSTM_STS_DOW 1 "ON" 0 "OFF" ;
VAL_ 552 RDR228_3_3_CSTM_STS_DOW_SFT_POS 1 "ONLY_P" 0 "OTHER_THAN_R" ;
VAL_ 552 RDR228_3_6_CSTM_DSP_BSD_LCA_2ND 1 "ON" 0 "OFF" ;
VAL_ 552 RDR228_3_7_CSTM_DSP_RCTA 1 "ON" 0 "OFF" ;
VAL_ 552 RDR228_2_0_CSTM_DSP_DOW 1 "ON" 0 "OFF" ;
VAL_ 552 RDR228_2_1_EYE_LOCAL_BUS1_FAIL 1 "EYE LOCAL BUS1 FAIL" 0 "NORMAL" ;
VAL_ 552 RDR228_2_2_CSTM_DSP_DOW_SFT_POS 1 "ON" 0 "OFF" ;
VAL_ 552 RDR228_2_3_ELK_STOP_REQ_FLG 1 "ELK stop request flag" 0 "NORMAL" ;
VAL_ 552 RDR228_2_4_FAIL_RDRSYS 1 "FAIL" 0 "NORMAL" ;
VAL_ 552 RDR228_2_5_STOP_RDRSYS 1 "HALT" 0 "NORMAL" ;
VAL_ 552 RDR228_2_6_ON_OFF_RDRSYS 1 "ON" 0 "OFF" ;
VAL_ 552 RDR228_2_7_BLOCKAGE_FORMING 1 "BLOCKAGE" 0 "NORMAL" ;
VAL_ 552 RDR228_1_4_BATT_OFF_CAUSE 1 "OFF required" 0 "ON required" ;
VAL_ 552 RDR228_1_5_CSTM_GLO_1 1 "ON" 0 "OFF" ;
VAL_ 552 RDR228_1_6_CSTM_GLO_3 1 "ON" 0 "OFF" ;
VAL_ 552 RDR228_1_7_CSTM_GLO_2 1 "ON" 0 "OFF" ;
VAL_ 967 EYE3C7_7_3_WARN_ESCALATION_REQ 7 "Reserve" 6 "MSB_WARN_5" 5 "MSB_WARN_4" 4 "MSB_WARN_3" 3 "MSB_WARN_2" 2 "MSB_WARN_1" 1 "Standby" 0 "OFF" ;
VAL_ 967 EYE3C7_7_6_AEB_MSB_LINK 3 "MSB_AEB_REQ" 2 "MSB_WARN" 1 "Standby" 0 "OFF" ;
VAL_ 967 EYE3C7_4_0_LKS_DMS_COOPERATION 1 "ON" 0 "OFF" ;
VAL_ 967 EYE3C7_4_1_LKS_ACTIVE 1 "ON" 0 "OFF" ;
VAL_ 967 EYE3C7_2_0_ALC_CONTROL 1 "ON" 0 "OFF" ;
VAL_ 967 EYE3C7_2_1_WINKER_OFF_REQ 1 "ON" 0 "OFF" ;
VAL_ 967 EYE3C7_2_2_HORN_HAZARD_ON_REQ 3 "Horn_On" 2 "HornHazard_On" 1 "Hazard_On" 0 "Off" ;
VAL_ 967 EYE3C7_2_4_DR_UNLOCK_REQ 1 "ドアアンロック要求" 0 "要求なし" ;
VAL_ 967 EYE3C7_2_5_WINKER_ON_REQ 3 "OFF_Request" 2 "Turn_Right_Request" 1 "Turn_Left_Request" 0 "OFF" ;
VAL_ 967 EYE3C7_2_7_MRM_ACTIVE 1 "ON" 0 "OFF" ;
VAL_ 964 EYE3C4_7_0_PCR_FAIL_OFF_IND 3 "No_Definition" 2 "FAIL" 1 "HALT/Customize OFF" 0 "NORMAL" ;
VAL_ 964 EYE3C4_7_2_AES_FAIL_OFF_IND 3 "No_Definition" 2 "FAIL" 1 "HALT/Customize OFF" 0 "NORMAL" ;
VAL_ 964 EYE3C4_7_4_LDP_FAIL_OFF_IND 3 "No_Definition" 2 "FAIL" 1 "HALT/Customize OFF" 0 "NORMAL" ;
VAL_ 964 EYE3C4_7_6_ELK_FAIL_OFF_IND 3 "No_Definition" 2 "FAIL" 1 "HALT/Customize OFF" 0 "NORMAL" ;
VAL_ 964 EYE3C4_6_0_MCAM_SYS_FAIL_HALT 3 "No_Definition" 2 "FAIL" 1 "HALT" 0 "NORMAL" ;
VAL_ 964 EYE3C4_6_2_MCAM_FUNC_INFO 1 "ON" 0 "OFF" ;
VAL_ 964 EYE3C4_6_3_EYE_DRV_ACTION_REQ 7 "No_Definition" 6 "No_Definition" 5 "No_Definition" 4 "restriction2" 3 "restriction1" 2 "permission" 1 "Prohibition" 0 "No Requirement" ;
VAL_ 964 EYE3C4_6_6_LDW_SND_OFF_FAIL_IND 3 "No_Definition" 2 "FAIL" 1 "OFF" 0 "TURN OFF" ;
VAL_ 964 EYE3C4_5_0_EAM_GREEN 3 "PATTERN3" 2 "PATTERN2" 1 "PATTERN1" 0 "TURN_OFF" ;
VAL_ 964 EYE3C4_5_2_EAM_BLUE 3 "PATTERN3" 2 "PATTERN2" 1 "PATTERN1" 0 "TURN_OFF" ;
VAL_ 964 EYE3C4_5_4_EAM_GREEN_2 3 "No_Definition" 2 "BLINK" 1 "ON" 0 "OFF" ;
VAL_ 964 EYE3C4_5_6_FCW_SND_OFF_FAIL_IND 3 "No_Definition" 2 "FAIL" 1 "OFF" 0 "TURN OFF" ;
VAL_ 964 EYE3C4_4_0_EAM_YELLOW 15 "No Definition" 14 "No_Definition" 13 "No_Definition" 12 "No_Definition" 11 "No_Definition" 10 "No_Definition" 9 "No_Definition" 8 "No_Definition" 7 "PATTERN⑦" 6 "PATTERN⑥" 5 "PATTERN⑤" 4 "PATTERN④" 3 "PATTERN③" 2 "PATTERN②" 1 "PATTERN①" 0 "TURN_OFF" ;
VAL_ 964 EYE3C4_4_4_EAM_RED 15 "No Definition" 14 "No_Definition" 13 "No_Definition" 12 "No_Definition" 11 "No_Definition" 10 "No_Definition" 9 "No_Definition" 8 "No_Definition" 7 "PATTERN⑦" 6 "PATTERN⑥" 5 "PATTERN⑤" 4 "PATTERN④" 3 "PATTERN③" 2 "PATTERN②" 1 "PATTERN①" 0 "TURN_OFF" ;
VAL_ 964 EYE3C4_3_0_CODE_NO_BUZZER 255 "Pattern255" 90 "Pattern90" 89 "Pattern89" 88 "Pattern88" 87 "Pattern87" 86 "Pattern86" 84 "Pattern84" 83 "Pattern83" 82 "Pattern82" 81 "Pattern81" 80 "Pattern80" 79 "Pattern79" 78 "Pattern78" 77 "Pattern77" 76 "Pattern76" 75 "Pattern75" 74 "Pattern74" 73 "Pattern73" 72 "Pattern72" 71 "Pattern71" 70 "Pattern70" 69 "Pattern69" 68 "Pattern68" 67 "Pattern67" 66 "Pattern66" 65 "Pattern65" 64 "Pattern64" 63 "Pattern63" 62 "Pattern62" 61 "Pattern61" 60 "Pattern60" 59 "Pattern59" 49 "Pattern49" 48 "Pattern48" 47 "Pattern47" 46 "Pattern46" 45 "Pattern45" 44 "Pattern44" 43 "Pattern43" 42 "Pattern42" 41 "Pattern41" 40 "Pattern40" 39 "Pattern39" 38 "Pattern38" 37 "Pattern37" 36 "Pattern36" 35 "Pattern35" 34 "Pattern34" 33 "Pattern33" 32 "Pattern32" 31 "Pattern31" 30 "Pattern30" 29 "Pattern29" 28 "Pattern28" 27 "Pattern27" 26 "Pattern26" 25 "Pattern25" 24 "Pattern24" 23 "Pattern23" 22 "Pattern22" 21 "Pattern21" 20 "Pattern20" 19 "Pattern19" 18 "Pattern18" 17 "Pattern17" 16 "Pattern16" 15 "Pattern15" 14 "Pattern14" 13 "Pattern13" 12 "Pattern12" 11 "Pattern11" 10 "Pattern10" 9 "Pattern9" 8 "Pattern8" 7 "Pattern7" 6 "Pattern6" 5 "Pattern5" 4 "Pattern4" 3 "Pattern3" 2 "Pattern2" 1 "Pattern1" 0 "OFF" ;
VAL_ 964 EYE3C4_2_0_CODE_WARN 255 "Pattern255" 166 "Pattern166" 165 "Pattern165" 164 "Pattern164" 163 "Pattern163" 162 "Pattern162" 161 "Pattern161" 160 "Pattern160" 159 "Pattern159" 158 "Pattern158" 157 "Pattern157" 156 "Pattern156" 155 "Pattern155" 154 "Pattern154" 153 "Pattern153" 152 "Pattern152" 151 "Pattern151" 150 "Pattern150" 149 "Pattern149" 148 "Pattern148" 147 "Pattern147" 146 "Pattern146" 145 "Pattern145" 144 "Pattern144" 90 "Pattern90" 89 "Pattern89" 88 "Pattern88" 87 "Pattern87" 86 "Pattern86" 85 "Pattern85" 84 "Pattern84" 83 "Pattern83" 82 "Pattern82" 81 "Pattern81" 80 "Pattern80" 79 "Pattern79" 78 "Pattern78" 77 "Pattern77" 76 "Pattern76" 75 "Pattern75" 74 "Pattern74" 73 "Pattern73" 72 "Pattern72" 71 "Pattern71" 70 "Pattern70" 69 "Pattern69" 68 "Pattern68" 67 "Pattern67" 66 "Pattern66" 65 "Pattern65" 64 "Pattern64" 63 "Pattern63" 62 "Pattern62" 61 "Pattern61" 60 "Pattern60" 59 "Pattern59" 58 "Pattern58" 57 "Pattern57" 56 "Pattern56" 55 "Pattern55" 54 "Pattern54" 53 "Pattern53" 52 "Pattern52" 51 "Pattern51" 50 "Pattern50" 49 "Pattern49" 48 "Pattern48" 47 "Pattern47" 46 "Pattern46" 45 "Pattern45" 44 "Pattern44" 43 "Pattern43" 42 "Pattern42" 41 "Pattern41" 40 "Pattern40" 39 "Pattern39" 38 "Pattern38" 37 "Pattern37" 36 "Pattern36" 35 "Pattern35" 34 "Pattern34" 33 "Pattern33" 32 "Pattern32" 31 "Pattern31" 30 "Pattern30" 29 "Pattern29" 28 "Pattern28" 27 "Pattern27" 26 "Pattern26" 25 "Pattern25" 24 "Pattern24" 23 "Pattern23" 22 "Pattern22" 21 "Pattern21" 20 "Pattern20" 19 "Pattern19" 18 "Pattern18" 17 "Pattern17" 16 "Pattern16" 15 "Pattern15" 14 "Pattern14" 13 "Pattern13" 12 "Pattern12" 11 "Pattern11" 10 "Pattern10" 9 "Pattern9" 8 "Pattern8" 7 "Pattern7" 6 "Pattern6" 5 "Pattern5" 4 "Pattern4" 3 "Pattern3" 2 "Pattern2" 1 "Pattern1" 0 "OFF" ;
VAL_ 964 EYE3C4_1_5_SNR_DRV_ACTION_REQ 7 "No_Definition" 6 "No_Definition" 5 "No_Definition" 4 "Restriction2" 3 "Restriction1" 2 "Permission" 1 "Prohibition" 0 "No Requirement" ;
VAL_ 554 EYE22A_2_0_PERMIT_ADB 1 "Hi" 0 "Lo" ;
VAL_ 554 EYE22A_2_1_HBA_MODE 1 "Hi" 0 "Lo" ;
VAL_ 554 EYE22A_2_2_PROCEEDING 1 "Hi" 0 "Lo" ;
VAL_ 554 EYE22A_2_3_ONCOMING 1 "ON" 0 "OFF" ;
VAL_ 554 EYE22A_2_4_OBJ_LEFTMOST 1 "ONCOMING" 0 "NOT_ONCOMING" ;
VAL_ 554 EYE22A_2_5_OBJ_RIGHTMOST 1 "ONCOMING" 0 "NOT_ONCOMING" ;
VAL_ 554 EYE22A_2_6_SENSITIVITY_SETTING 1 "Sensitivity_Setting" 0 "Normal" ;
VAL_ 554 EYE22A_2_7_AHL_DATAFAIL_FLG 1 "Turn_ON" 0 "Turn_OFF" ;
VAL_ 554 EYE22A_1_4_FAIL 1 "FAIL" 0 "OFF" ;
VAL_ 554 EYE22A_1_5_INIT_END 1 "ON" 0 "OFF" ;
VAL_ 554 EYE22A_1_6_HALT 1 "HALT" 0 "OFF" ;
VAL_ 916 ADAS394_2_2_STRGECU_FAIL 1 "DETECT" 0 "NON_DETECT" ;
VAL_ 916 ADAS394_2_1_STRGHTR_OPEN_FAIL 1 "DETECT" 0 "NON_DETECT" ;
VAL_ 916 ADAS394_2_0_STRGHTR_SHORT_FAIL 1 "DETECT" 0 "NON_DETECT" ;
VAL_ 916 ADAS394_1_7_COMM_STRGECU 1 "Fail" 0 "Normal" ;
VAL_ 916 ADAS394_1_4_STRGHTR_STATE 3 "Reserve" 2 "LOW" 1 "HIGH" 0 "OFF" ;
VAL_ 857 THM359_5_1_HVBOUTLTEMPREL 3 "正常" 2 "異常" 1 "仮異常" 0 "未確定" ;
VAL_ 857 THM359_3_1_HVBINLTEMPREL 3 "正常" 2 "異常" 1 "仮異常" 0 "未確定" ;
VAL_ 857 THM359_3_3_IJDRMDTRFREQ 1 "注排水移行要求あり" 0 "注排水移行要求なし" ;
VAL_ 855 THM357_6_0_ACNINVINI 1 "マイコンリセット後" 0 "通常作動可能時 " ;
VAL_ 855 THM357_6_1_THMADJRSVCCSSTT 7 "RESERVED" 6 "RESERVED" 5 "RESERVED" 4 "RESERVED" 3 "RESERVED" 2 "RESERVED" 1 "ON" 0 "OFF" ;
VAL_ 855 THM357_5_0_NVLMT 1 "禁止" 0 "許可" ;
VAL_ 855 THM357_5_1_ACNHVDDRVADM 1 "許可" 0 "非許可" ;
VAL_ 855 THM357_4_0_INVCPUABN 1 "エラー検出時" 0 "正常時 " ;
VAL_ 855 THM357_4_2_ACNINIEXEADM 1 "許可" 0 "禁止" ;
VAL_ 855 THM357_4_3_ACNINHSIG 1 "許可" 0 "禁止" ;
VAL_ 855 THM357_4_4_DRVBATCLG 1 "ON" 0 "OFF" ;
VAL_ 855 THM357_4_5_DRVBATWRM 1 "ON" 0 "OFF" ;
VAL_ 855 THM357_4_6_OILCLCTADM 3 "未使用" 2 "未使用" 1 "可" 0 "否" ;
VAL_ 854 THM356_7_0_INVTEMPSNSABN 1 "Temperature sensor Error (温度センサ異常)" 0 "No error (異常なし)" ;
VAL_ 854 THM356_7_1_STBSTT 1 "ON" 0 "OFF" ;
VAL_ 854 THM356_7_2_INVINTERR 3 "Over Load (過負荷)" 2 "Output Line Open Contact (出力断線) " 1 "Output Line Short  circuit (出力ショート)" 0 "No error (異常なし)" ;
VAL_ 854 THM356_7_4_SELFINVCHK 1 "SECHON(ｲﾝﾊﾞｰﾀの故障)" 0 "SECHOFF(正常)" ;
VAL_ 854 THM356_7_5_INVINTPWRABN 3 "未定義 " 2 "制御電源系 内部電源異常 " 1 "未定義 " 0 "制御電源系 正常 " ;
VAL_ 854 THM356_6_0_INVCURSNSABN 1 "Current sensor Error (電流センサ異常)" 0 "No error (異常なし)" ;
VAL_ 854 THM356_6_1_ACNMOTCTRLABN 3 "A/C System Error (システム異常停止)" 2 "Software Over Current (ソフト過電流)" 1 "Start Fail (起動失敗)" 0 "No error (異常なし)" ;
VAL_ 854 THM356_6_3_ACNCMNSTT_INV 1 "ACICON(サムチェックエラーが５回以上)or(統合ECU→ACインバータ間通信異常)" 0 "ACICOFF(正常時)" ;
VAL_ 854 THM356_6_4_CMPSTT 7 "( Reserved )" 6 "( Reserved )" 5 "Comp out of range (要求回転数異常)" 4 "Comp shutdown (復帰不可異常)" 3 "Comp Stopped (復帰可能異常) " 2 "Comp degraded (コンプレッサ制限運転)" 1 "Comp on (コンプレッサ動作)" 0 "Comp off (コンプレッサ停止)" ;
VAL_ 854 THM356_6_7_RESLOTEMPABN 1 "THCT ON（ｻｰﾐｽﾀが動作保証温度以下）" 0 "THCT OFF(正常) " ;
VAL_ 854 THM356_5_2_FRCDAIRCYCLREQ 1 "要求あり" 0 "要求なし" ;
VAL_ 854 THM356_5_3_ACNCMNSTT_ICU 1 "ON" 0 "OFF" ;
VAL_ 854 THM356_5_4_INVMAINVLTDIAG 3 "主電源電圧がHVｼｽﾃﾑ故障範囲" 2 "主電源電圧が正常範囲以上" 1 "主電源電圧が範囲未満" 0 "主電源電圧正常範囲内にある" ;
VAL_ 854 THM356_5_6_INVOVRHEAT 3 "(Reserved)" 2 "Over heat warning (オーバーヒートによる保護停止(過熱S))" 1 "Low temperature warning (低温警報)" 0 "No error(異状なし)" ;
VAL_ 853 THM355_6_0_LTCRFNWASTCALRLV 7 "未定義" 6 "未定義" 5 "DC-Lv2" 4 "DC-Lv1" 3 "通常-Lv3" 2 "通常-Lv2" 1 "通常-Lv1" 0 "Lv0" ;
VAL_ 853 THM355_6_3_ACNOVRLDSTT 3 "未定義" 2 "過負荷警報　領域2" 1 "過負荷警報　領域１" 0 "異常なし" ;
VAL_ 853 THM355_6_5_STRTLMTSTT 1 "制限中" 0 "未実施" ;
VAL_ 853 THM355_6_6_DLYSTRTSTT 1 "完了" 0 "未実施" ;
VAL_ 853 THM355_5_7_HVHLKCHKOPEREQ 1 "ON" 0 "OFF" ;
VAL_ 853 THM355_3_2_HVHSTBOP 1 "ON" 0 "OFF" ;
VAL_ 853 THM355_3_4_HVHSTBSTT 3 "噛みこみあり" 2 "STB ON" 1 "STB OFF" 0 "未確定" ;
VAL_ 853 THM355_3_6_HVHOPEHLD 3 "(定義なし)" 2 "保持実施中" 1 "保持待機中" 0 "停止" ;
VAL_ 852 THM354_7_0_HVHCLTPHI 1 "警告" 0 "異常無し" ;
VAL_ 852 THM354_7_5_HVHOVHTSTT 1 "あり" 0 "なし" ;
VAL_ 852 THM354_7_7_HVHINTCMNABN 1 "警告" 0 "異常無し" ;
VAL_ 852 THM354_2_0_HVHIGBTABN 1 "異常有り" 0 "異常無し" ;
VAL_ 852 THM354_2_1_HVHSTBSTT 3 "噛みこみあり" 2 "STBON" 1 "STBOFF" 0 "未確定" ;
VAL_ 852 THM354_2_3_HVHMEMABN 1 "異常有り" 0 "異常無し" ;
VAL_ 852 THM354_2_4_HVHSERVREQ 1 "異常有り" 0 "異常無し" ;
VAL_ 852 THM354_2_5_HVHSTTFBK 7 "Resesrved" 6 "Resesrved" 5 "Resesrved" 4 "通常動作モード" 3 "永久ロック" 2 "サービスまでロック" 1 "次回起動までロック" 0 "OFF" ;
VAL_ 852 THM354_1_4_HVHINLCLTPABN 1 "異常有り" 0 "正常" ;
VAL_ 852 THM354_1_5_HVHOUTLCLTPABN 1 "異常有り" 0 "正常" ;
VAL_ 852 THM354_1_6_HVHOVHTABN 1 "異常有り" 0 "正常" ;
VAL_ 851 THM353_7_5_LTCHTGLV 7 "Lv7" 6 "Lv6" 5 "Lv5" 4 "Lv4" 3 "Lv3" 2 "Lv2" 1 "Lv1" 0 "昇温要求無し" ;
VAL_ 851 THM353_3_3_LTCCLGLV 7 "Lv7" 6 "Lv6" 5 "Lv5" 4 "Lv4" 3 "Lv3" 2 "Lv2" 1 "Lv1" 0 "冷却要求無し" ;
VAL_ 851 THM353_3_6_DEFRANS 1 "受諾" 0 "未受諾" ;
VAL_ 851 THM353_3_7_CDVINIREQ 1 "要求あり" 0 "要求なし" ;
VAL_ 851 THM353_1_4_CHILCLTPCHNGSTT 3 "予備" 2 "急上昇" 1 "急低下" 0 "通常" ;
VAL_ 850 THM352_7_2_HVHOVHTSTT 1 "あり" 0 "なし" ;
VAL_ 850 THM352_7_4_HVHINLCLTPABN 1 "異常有り" 0 "正常" ;
VAL_ 850 THM352_7_5_HVHOUTLCLTPABN 1 "異常有り" 0 "正常" ;
VAL_ 850 THM352_7_6_HVHOVHTABN 1 "異常有り" 0 "正常" ;
VAL_ 850 THM352_7_7_HVHLINABN 1 "通信エラー" 0 "正常" ;
VAL_ 850 THM352_5_3_LTCCHNGREQ 13 "チラー熱移動なし_HT_LT間熱移動なし" 12 "チラー熱移動なし_HT_LT間熱移動あり_除霜なし_PT通水あり" 11 "チラー熱移動なし_HT_LT間熱移動あり_除霜なし_PT通水なし" 10 "チラー熱移動なし_HT_LT間熱移動あり_除霜あり" 9 "チラーLTラジエータ間熱移動あり_HT_LT間熱移動なし" 8 "チラー電池間熱移動あり_HT_LT間熱移動なし" 7 "チラーLTデバイス間熱移動あり_HT_LT間熱移動なし_水水HEX通水あり" 6 "チラーLTデバイス間熱移動あり_HT_LT間熱移動なし_水水HEX通水なし" 5 "チラーLTラジエータ間熱移動あり_HT_LT間熱移動あり" 4 "チラー水水HEX間熱移動あり_HT_LT間熱移動あり_電池＆PT通水あり" 3 "チラー水水HEX間熱移動あり_HT_LT間熱移動あり_電池＆PT通水なし" 2 "チラー電池間熱移動あり_HT_LT間熱移動あり_除霜なし" 1 "チラー電池間熱移動あり_HT_LT間熱移動あり_除霜あり" 0 "回路不明_移行要求無し" ;
VAL_ 850 THM352_4_6_LTCSTT 13 "チラー熱移動なし_HT_LT間熱移動なし" 12 "チラー熱移動なし_HT_LT間熱移動あり_除霜なし_PT通水あり" 11 "チラー熱移動なし_HT_LT間熱移動あり_除霜なし_PT通水なし" 10 "チラー熱移動なし_HT_LT間熱移動あり_除霜あり" 9 "チラーLTラジエータ間熱移動あり_HT_LT間熱移動なし" 8 "チラー電池間熱移動あり_HT_LT間熱移動なし" 7 "チラーLTデバイス間熱移動あり_HT_LT間熱移動なし_水水HEX通水あり" 6 "チラーLTデバイス間熱移動あり_HT_LT間熱移動なし_水水HEX通水なし" 5 "チラーLTラジエータ間熱移動あり_HT_LT間熱移動あり" 4 "チラー水水HEX間熱移動あり_HT_LT間熱移動あり_電池＆PT通水あり" 3 "チラー水水HEX間熱移動あり_HT_LT間熱移動あり_電池＆PT通水なし" 2 "チラー電池間熱移動あり_HT_LT間熱移動あり_除霜なし" 1 "チラー電池間熱移動あり_HT_LT間熱移動あり_除霜あり" 0 "回路不明_移行要求無し" ;
VAL_ 850 THM352_2_0_RFRCCHNGREQ 8 "冷媒-D-3_チラー_廃熱HP暖房" 7 "冷媒-D-2_チラー_電池冷却有" 6 "冷媒-D-1_チラー_外気HP_TL" 5 "冷媒-C_OFF" 4 "冷媒-B-3_エバ_チラー_廃熱HP暖房" 3 "冷媒-B-2_エバ_チラー_電池冷却有" 2 "冷媒-B-1_エバ_チラー_外気HP_TL" 1 "冷媒-A_エバ" 0 "移行要求無し" ;
VAL_ 850 THM352_2_4_CHILCLTPCHNGSTT 3 "予備" 2 "水温下降" 1 "水温上昇" 0 "変動なし" ;
VAL_ 850 THM352_1_4_HVHPRTRUN 1 "有り" 0 "無し" ;
VAL_ 850 THM352_1_5_BWPSTRTFLG 1 "動作中" 0 "停止" ;
VAL_ 850 THM352_1_6_EXSTTEMPABN 1 "異常" 0 "正常" ;
VAL_ 1537 BEV601_2_0_IMBSTS 1 "セット" 0 "アンセット" ;
VAL_ 1537 BEV601_2_1_RDYNGSTS 3 "未定義" 2 "不可(異常)" 1 "不可" 0 "OFF" ;
VAL_ 1537 BEV601_1_4_CDEVANS 1 "ON" 0 "OFF" ;
VAL_ 267 BEV10B_6_7_SPEC8 1 "PERMIT" 0 "INHIBIT" ;
VAL_ 267 BEV10B_6_6_SPEC7 1 "PERMIT" 0 "INHIBIT" ;
VAL_ 267 BEV10B_6_5_SPEC6 1 "PERMIT" 0 "INHIBIT" ;
VAL_ 267 BEV10B_6_4_SPEC5 1 "PERMIT" 0 "INHIBIT" ;
VAL_ 267 BEV10B_6_3_SPEC4 1 "PERMIT" 0 "INHIBIT" ;
VAL_ 267 BEV10B_6_2_SPEC3 1 "PERMIT" 0 "INHIBIT" ;
VAL_ 267 BEV10B_6_1_SPEC2 1 "PERMIT" 0 "INHIBIT" ;
VAL_ 267 BEV10B_6_0_SPEC1 1 "PERMIT" 0 "INHIBIT" ;
VAL_ 267 BEV10B_5_2_DENO 1 "PERMIT" 0 "INHIBIT" ;
VAL_ 267 BEV10B_5_1_PROHIBIT_INC 1 "INHIBIT" 0 "PERMIT" ;
VAL_ 267 BEV10B_5_0_PERMIT_INC 1 "PERMIT" 0 "INHIBIT" ;
VAL_ 267 BEV10B_3_2_OBDRDY 1 "OBDReady-ON" 0 "OBDReady-OFF" ;
VAL_ 267 BEV10B_3_0_DRVRDY 3 "Undefine" 2 "Turn_ON" 1 "Flash" 0 "Turn_Off" ;
VAL_ 116 BEV074_7_0_LVPWRDWN 3 "抑制レベル3" 2 "抑制レベル2" 1 "抑制レベル1" 0 "抑制要求なし" ;
VAL_ 116 BEV074_7_6_CHRCONSTA 1 "Connected" 0 "NotConnected" ;
VAL_ 116 BEV074_7_7_VEHICLE_IGN 1 "ON" 0 "OFF" ;
VAL_ 116 BEV074_6_0_EV_CAU 3 "Undefine" 2 "Flash" 1 "Turn_On" 0 "Turn_Off" ;
VAL_ 116 BEV074_6_2_BEV_OBD_CAU 7 "Undefine" 6 "Undefine" 5 "Undefine" 4 "Initial_Check" 3 "Flash_3Hz" 2 "Flash_1Hz" 1 "Turn_On" 0 "Turn_Off" ;
VAL_ 116 BEV074_6_5_SIDRIVE_DISP 7 "PreS#" 6 "S#_TADAN" 5 "X(DEEP SNOW・MUD)" 4 "X(SNOW･DIRT)" 3 "S" 2 "I" 1 "S#" 0 "TURN_OFF" ;
VAL_ 116 BEV074_5_0_ACCHG_STATE 1 "充電実施中" 0 "充電未実施" ;
VAL_ 116 BEV074_5_1_DCCHG_STATE 1 "DC充電実施中" 0 "DC充電未実施" ;
VAL_ 116 BEV074_5_2_RANGE_DG 1 "異常" 0 "正常" ;
VAL_ 116 BEV074_5_3_ACCP_DG 1 "ON" 0 "OFF" ;
VAL_ 116 BEV074_5_4_REZ_SPD_BK 3 "FS固定値" 2 "FSバックアップ値(符号無し)" 1 "FSバックアップ値" 0 "センサ値" ;
VAL_ 116 BEV074_5_6_OBDRDY 1 "Ready-ON" 0 "Ready-OFF" ;
VAL_ 116 BEV074_5_7_FHVB 1 "ON" 0 "OFF" ;
VAL_ 116 BEV074_3_0_RANGE_POS 7 "未定義" 6 "blank" 5 "未定義" 4 "B" 3 "D" 2 "N" 1 "R" 0 "P" ;
VAL_ 116 BEV074_3_3_DRVRDY 3 "Undefine" 2 "Turn_ON" 1 "Flash" 0 "Turn_Off" ;
VAL_ 116 BEV074_3_5_HVSYSTS 3 "停止処理中" 2 "起動処理中" 1 "起動" 0 "停止" ;
VAL_ 116 BEV074_1_4_RANGE_DG2 1 "異常" 0 "正常" ;
VAL_ 116 BEV074_1_5_REZ_SPD_BK 5 "FS固定値" 4 "RrFSバックアップ値(符号無し)" 3 "FrFSバックアップ値(符号無し)" 2 "Rrセンサ値" 1 "Frセンサ値" 0 "FrRrセンサ値" ;
VAL_ 1880 RBB758_0_0_DIAG_N_TA 147 "P/W_RL(HR3)" 146 "P/W_RR(HR3)" 145 "P/W_P(HR3)" 144 "P/W_D(HR3)" 125 "POWER_REAR_GATE_(BF4)" 176 "RAIN_SENSOR_(BF4/HR3)" 171 "MEMORY_SHEET_D_(BF4)" 197 "IMPACT_SENSOR_(FM5/BF4/HR3)" 236 "P/W_(AS1)" 233 "SMT_(AS1)" 181 "SMT_(AS1)" 64 "BIU_(AS1)" 42 "TPMS_(AS1)" ;
VAL_ 1872 DNT750_0_0_DIAG_N_TA 147 "P/W_RL(HR3)" 146 "P/W_RR(HR3)" 145 "P/W_P(HR3)" 144 "P/W_D(HR3)" 193 "IMMOBILIZER_ECU_(BF4/HR3)" 125 "POWER_REAR_GATE_(BF4)" 176 "RAIN_SENSOR_(BF4/HR3)" 171 "MEMORY_SHEET_D_(BF4)" 198 "ULTRA_SONIC_SENSOR_(BF4)" 197 "IMPACT_SENSOR_(FM5/BF4/HR3)" 236 "P/W_(AS1)" 233 "SMT_(AS1)" 181 "SMT_(AS1)" 64 "BIU_(AS1)" 42 "TPMS_(AS1)" ;
VAL_ 1774 CECU6EE_7_0_DESTINATION_INFO 3 "EUROPE_LH" 2 "EUROPE_RH" 1 "DOMESTIC" 0 "US_CANADA" ;
VAL_ 1774 CECU6EE_7_4_VEHICLE_SERIES 7 "NON" 6 "VEHICLE_W" 5 "VEHICLE_V" 4 "VEHICLE_Z" 3 "VEHICLE_S" 2 "VEHICLE_G" 1 "VEHICLE_B" 0 "DEFAULT" ;
VAL_ 1774 CECU6EE_6_0_DESTINATION_CODE 37 "NON" 36 "KR" 35 "KF" 34 "K2" 33 "C6" 32 "U7" 31 "E5" 30 "KG" 29 "E1" 28 "KE" 27 "KP" 26 "EH" 25 "E9" 24 "C4" 23 "KC" 22 "KV" 21 "KY" 20 "KA" 19 "EN" 18 "ER" 17 "EP" 16 "KS" 15 "K4" 14 "E3" 13 "EA" 12 "E7" 11 "ES" 10 "E2" 9 "EE" 8 "EK" 7 "C5" 6 "U5" 5 "EC" 4 "CO" 3 "U4" 2 "JPN" 1 "NON" 0 "DEFAULT" ;
VAL_ 1774 CECU6EE_5_0_EYE_VERSION_INFO 3 "VER4_HEIGHT_DRIVING_ASSIST" 2 "VER4" 1 "NO_EYE" 0 "DEFAULT" ;
VAL_ 1774 CECU6EE_5_4_VEHICLE_TYPE 1 "WGN" 0 "SDN" ;
VAL_ 1774 CECU6EE_5_6_PRODUCTION_BASE 1 "SIA" 0 "DOMESTIC" ;
VAL_ 1774 CECU6EE_4_2_WHEEL_DRIVE_TYPE 1 "4WD" 0 "FF" ;
VAL_ 1774 CECU6EE_4_3_3RD_SHEAT_EQUIPMENT 1 "EQUIPPED" 0 "NO_EQUIPPED" ;
VAL_ 1774 CECU6EE_4_4_FLG_XMODE 3 "X_MODE_2_MODE" 2 "X_MODE_1_MODE" 1 "NO_X_MODE" 0 "DEFAULT" ;
VAL_ 1774 CECU6EE_4_6_ISS_EQUIPMENT 1 "EQUIPPED" 0 "NO_EQUIPPED" ;
VAL_ 1773 CECU6ED_7_0_VEHICLE_TYPE_DETAIL 15 "NON" 14 "NON" 13 "NON" 12 "NON" 11 "NON" 10 "NON" 9 "NON" 8 "NON" 7 "COUPE" 6 "3RD_ROW_SUV" 5 "XUV" 4 "5D" 3 "OUTBACK" 2 "WGN" 1 "SD" 0 "DEFAULT" ;
VAL_ 1773 CECU6ED_5_0_TRANSMISSION_TYPE 1 "MT" 0 "CVT" ;
VAL_ 1773 CECU6ED_5_4_HANDLE 1 "RHD" 0 "LHD" ;
VAL_ 1773 CECU6ED_4_0_VEHICLE_HEIGHT 7 "NON" 6 "LIFT4" 5 "LIFT3" 4 "LIFT2" 3 "Wilderness" 2 "LIFT" 1 "STANDARD" 0 "DEFAULT" ;
VAL_ 1773 CECU6ED_4_4_SEATHEATER_EQUIPMENT 3 "SEAT_HEATER_D_P_REAR" 2 "SEAT_HEATER_D_P" 1 "NOT_SEAT_HEATER" 0 "DEFAULT" ;
VAL_ 1773 CECU6ED_3_0_YEAR_CHANGE 15 "NON" 14 "NON" 13 "NON" 12 "NON" 11 "NON" 10 "9" 9 "8" 8 "7" 7 "6" 6 "5" 5 "4" 4 "3" 3 "2" 2 "1" 1 "0" 0 "DEFAULT" ;
VAL_ 1773 CECU6ED_3_4_HEV_INFO 7 "NON" 6 "NON" 5 "BEV" 4 "SHEV" 3 "MHEV" 2 "PHEV" 1 "CONVE" 0 "DEFAULT" ;
VAL_ 1772 CECU6EC_6_0_SMT_EQUIPMENT 1 "EQUIPPED" 0 "NO_EQUIPPED" ;
VAL_ 1772 CECU6EC_6_1_DCCD_EQUIPMENT 1 "EQUIPPED" 0 "NO_EQUIPPED" ;
VAL_ 1772 CECU6EC_5_0_CCU_EQUIPMENT 1 "EQUIPPED" 0 "NO_EQUIPPED" ;
VAL_ 1772 CECU6EC_5_1_EAM_EQUIPMENT 1 "EQUIPPED" 0 "NO_EQUIPPED" ;
VAL_ 1772 CECU6EC_5_2_RCR_L_EQUIPMENT 1 "EQUIPPED" 0 "NO_EQUIPPED" ;
VAL_ 1772 CECU6EC_5_3_RCR_R_EQUIPMENT 1 "EQUIPPED" 0 "NO_EQUIPPED" ;
VAL_ 1772 CECU6EC_5_4_FCR_L_EQUIPMENT 1 "EQUIPPED" 0 "NO_EQUIPPED" ;
VAL_ 1772 CECU6EC_5_5_FCR_R_EQUIPMENT 1 "EQUIPPED" 0 "NO_EQUIPPED" ;
VAL_ 1772 CECU6EC_5_6_VSS_EQUIPMENT 1 "EQUIPPED" 0 "NO_EQUIPPED" ;
VAL_ 1772 CECU6EC_5_7_RES_EQUIPMENT 1 "EQUIPPED" 0 "NO_EQUIPPED" ;
VAL_ 1772 CECU6EC_4_0_LCT_EQUIPMENT 1 "EQUIPPED" 0 "NO_EQUIPPED" ;
VAL_ 1772 CECU6EC_4_1_DAM_EQUIPMENT 1 "EQUIPPED" 0 "NO_EQUIPPED" ;
VAL_ 1772 CECU6EC_4_2_MVS_EQUIPMENT 1 "EQUIPPED" 0 "NO_EQUIPPED" ;
VAL_ 1772 CECU6EC_4_3_TCU_EQUIPMENT 1 "EQUIPPED" 0 "NO_EQUIPPED" ;
VAL_ 1772 CECU6EC_4_4_TPM_EQUIPMENT 1 "EQUIPPED" 0 "NO_EQUIPPED" ;
VAL_ 1772 CECU6EC_4_5_DCM_EQUIPMENT 1 "EQUIPPED" 0 "NO_EQUIPPED" ;
VAL_ 1772 CECU6EC_4_6_MED_EQUIPMENT 1 "EQUIPPED" 0 "NO_EQUIPPED" ;
VAL_ 1772 CECU6EC_4_7_MEP_EQUIPMENT 1 "EQUIPPED" 0 "NO_EQUIPPED" ;
VAL_ 1772 CECU6EC_3_0_DATA_STATE 1 "ABNORMAL" 0 "NORMAL" ;
VAL_ 1772 CECU6EC_3_1_EYE_EQUIPMENT 1 "EQUIPPED" 0 "NO_EQUIPPED" ;
VAL_ 1772 CECU6EC_3_2_HEV_EQUIPMENT 1 "EQUIPPED" 0 "NO_EQUIPPED" ;
VAL_ 1772 CECU6EC_3_3_SNR_EQUIPMENT 1 "EQUIPPED" 0 "NO_EQUIPPED" ;
VAL_ 1772 CECU6EC_3_4_EPB_EQUIPMENT 1 "EQUIPPED" 0 "NO_EQUIPPED" ;
VAL_ 1772 CECU6EC_3_5_DMS_EQUIPMENT 1 "EQUIPPED" 0 "NO_EQUIPPED" ;
VAL_ 1772 CECU6EC_3_6_BST_EQUIPMENT 1 "EQUIPPED" 0 "NO_EQUIPPED" ;
VAL_ 1772 CECU6EC_3_7_MCA_EQUIPMENT 1 "EQUIPPED" 0 "NO_EQUIPPED" ;
VAL_ 1735 CECU6C7_5_0_BLOWERFAN_SETTING 7 "Hi" 6 "M5" 5 "M4" 4 "M3" 3 "M2" 2 "M1" 1 "Lo" 0 "Default" ;
VAL_ 1735 CECU6C7_5_3_STEERING_HTR_AUTO 1 "ON" 0 "OFF" ;
VAL_ 1735 CECU6C7_5_4_DR_SEAT_HTR_AUTO 1 "ON" 0 "OFF" ;
VAL_ 1735 CECU6C7_5_5_PA_SEAT_HTR_AUTO 1 "ON" 0 "OFF" ;
VAL_ 1735 CECU6C7_4_0_Dr_TEMP_SETTING 63 "Default" 44 "Hi" 43 "34.5℃(99°F)" 1 "13.5℃(57°F)" 0 "Low" ;
VAL_ 1735 CECU6C7_4_6_FT_ACN_SETTING 1 "ON" 0 "OFF" ;
VAL_ 1735 CECU6C7_4_7_RCC_RDEF_SETTING 1 "ON" 0 "OFF" ;
VAL_ 1735 CECU6C7_3_0_VENT_SETTING 21 "ALL FLOW" 6 "Def" 5 "F/D" 4 "Foot" 3 "B/L" 2 "VENT Ⅱ" 1 "VENT" 0 "Default" ;
VAL_ 1735 CECU6C7_3_4_CIRCULAION_SETTING 3 "Turn ON ALL" 2 "Outside Air" 1 "Recirculation" 0 "Default" ;
VAL_ 1735 CECU6C7_3_6_AUTO3_MODE 3 "HI" 2 "MI" 1 "LO" 0 "OFF" ;
VAL_ 1735 CECU6C7_2_0_DR_H_VENTI_SETTING 7 "VENT HI" 6 "VENT MI" 5 "VENT LO" 4 "UNDEFINED" 3 "HEATER HI" 2 "HEATER MI" 1 "HEATER LO" 0 "OFF" ;
VAL_ 1735 CECU6C7_2_3_PA_H_VENTI_SETTING 7 "VENT HI" 6 "VENT MI" 5 "VENT LO" 4 "UNDEFINED" 3 "HEATER HI" 2 "HEATER MI" 1 "HEATER LO" 0 "OFF" ;
VAL_ 1735 CECU6C7_2_6_STRG_H_SETTING 2 "High" 1 "Low" 0 "Stop" ;
VAL_ 1735 CECU6C7_1_4_RCC_SETTING_REQ 1 "Request" 0 "No_Request" ;
VAL_ 996 CECU3E4_7_0_SSM_COMM_INFO 1 "COMM_ON" 0 "COMM_OFF" ;
VAL_ 996 CECU3E4_6_0_CHARGE_LEVEL_ENG_RUN 9 "level10" 8 "level9" 7 "level8" 6 "level7" 5 "level6" 4 "level5" 3 "level4" 2 "level3" 1 "level2" 0 "level1" ;
VAL_ 996 CECU3E4_6_4_CHARGE_LEVEL_IGN_ON 9 "level10" 8 "level9" 7 "level8" 6 "level7" 5 "level6" 4 "level5" 3 "level4" 2 "level3" 1 "level2" 0 "level1" ;
VAL_ 996 CECU3E4_5_0_GENERATOR_OVER_FLG 3 "EvLoadRestrain2" 2 "EvLoadRestrain1" 1 "Overloaded" 0 "NormalState" ;
VAL_ 996 CECU3E4_5_3_DIAG_COM_REQ 1 "Diag_Com_Request" 0 "No_Request" ;
VAL_ 996 CECU3E4_5_4_HEADS_UP_FLG 1 "ChargeRequest" 0 "Normal" ;
VAL_ 996 CECU3E4_2_7_OCCUPATION_CSTM 1 "D_SEAT" 0 "ALL_SEATS" ;
VAL_ 1280 CGW500_1_4_ActiveWakeUpBit 1 "active wakeup" 0 "passive wakeup" ;
VAL_ 1632 CGW660_1_0_SUB_ID 65535 "NORMAL" ;
VAL_ 1744 CECU6D0_4_0_OTA_ABORT 1 "OTA中止" 0 "OTA中止でない" ;
VAL_ 1744 CECU6D0_4_1_OTA_SUSPEND 1 "OTA中断" 0 "OTA中断でない" ;
VAL_ 1744 CECU6D0_4_2_OTA_SEQUENCE 33170 "予備" 16534 "予備" 8264 "Campaignなし" 4132 "OTA完了" 1298 "SWID照合中" 598 "電源ON待ち" 296 "電源OFF待ち" 100 "Activate中(Dual)" 50 "Install中(Single)" 22 "アップデート適用開始待ち" 8 "アップデート適用承諾待ち" 4 "Install中(Dual)" 2 "Download中" 1 "Campaign情報取得中" 0 "未実施" ;
VAL_ 1743 DCM6CF_6_6_AACN_FLG 1 "AACN有" 0 "AACN無" ;
VAL_ 1743 DCM6CF_5_0_EMERGENCY_CALL_ON_OFF 1 "Emergency_call_ON" 0 "Emergency_call_OFF" ;
VAL_ 1743 DCM6CF_4_2_STR_HEATER_ON_OFF 1 "Steering_heater_ON" 0 "Steering_heater_OFF" ;
VAL_ 1743 DCM6CF_3_0_RES_CONTRACT_INFO 1 "ON" 0 "OFF" ;
VAL_ 1743 DCM6CF_3_1_REQ_ST_ON 1 "ON" 0 "OFF" ;
VAL_ 1743 DCM6CF_3_3_ON_SIGN 1 "ON" 0 "OFF" ;
VAL_ 1743 DCM6CF_3_5_REQ_PARKLIGHT_HORN 7 "NOT REQUEST" 6 "NOT REQUEST" 5 "NOT REQUEST" 4 "PARK LIGHT ON&HORN OFF" 3 "PARK LIGHT&HORN ANSWER BACK 3 TIME" 2 "PARK LIGHT&HORN ANSWER BACK 2 TIME" 1 "PARK LIGHT&HORN ANSWER BACK 1 TIME" 0 "NOT REQUEST" ;
VAL_ 1743 DCM6CF_2_1_DCM_FAILURE_STATUS 1 "at least one failure is detected" 0 "no failure is detected" ;
VAL_ 1743 DCM6CF_2_2_REQ_WINDOW_STATUS 1 "REQUEST" 0 "NOT_REQUEST" ;
VAL_ 1743 DCM6CF_1_6_DKY_PROV_STS 1 "ON" 0 "OFF" ;
VAL_ 1743 DCM6CF_1_7_PNC_PROV_STS 1 "ON" 0 "OFF" ;
VAL_ 1749 CECU6D5_6_0_CSTM_FMHD 7 "Undefined" 6 "Undefined" 5 "90sec" 4 "60sec" 3 "30sec" 2 "20sec" 1 "10sec" 0 "OFF" ;
VAL_ 1749 CECU6D5_5_0_CSTM_WRH 1 "ON" 0 "OFF" ;
VAL_ 1749 CECU6D5_5_1_CSTM_LMHD 3 "30sec" 2 "20sec" 1 "10sec" 0 "OFF" ;
VAL_ 1749 CECU6D5_5_5_CSTM_HBA 3 "Undefined" 2 "Undefined" 1 "ON" 0 "OFF" ;
VAL_ 1749 CECU6D5_5_7_ADB_ACTIVE 1 "ON" 0 "OFF" ;
VAL_ 1749 CECU6D5_4_0_JUDGE_ILL 1 "YES" 0 "NO" ;
VAL_ 1749 CECU6D5_4_1_HEADLAMP_AUTO_SW 1 "ON" 0 "OFF" ;
VAL_ 1749 CECU6D5_4_2_IND_ACTIVE_HBA 3 "Undefined" 2 "Blink" 1 "ON" 0 "OFF" ;
VAL_ 1749 CECU6D5_4_4_FGT_LGTOFF_WARNING 1 "ON" 0 "OFF" ;
VAL_ 1749 CECU6D5_3_0_CRN_R_REQ 3 "Undefined" 2 "ON" 1 "Faded OFF" 0 "OFF" ;
VAL_ 1749 CECU6D5_3_2_CRN_L_REQ 3 "Undefined" 2 "ON" 1 "Faded OFF" 0 "OFF" ;
VAL_ 1749 CECU6D5_3_4_FMH 1 "ON" 0 "OFF" ;
VAL_ 1749 CECU6D5_3_5_LMH 1 "ON" 0 "OFF" ;
VAL_ 1749 CECU6D5_2_0_LGT_1 1 "ON" 0 "OFF" ;
VAL_ 1749 CECU6D5_2_1_LGT_LO 1 "ON" 0 "OFF" ;
VAL_ 1749 CECU6D5_2_2_LGT_HI 1 "ON" 0 "OFF" ;
VAL_ 1749 CECU6D5_2_4_FFOG_RELAY_REQ 1 "ON" 0 "OFF" ;
VAL_ 1749 CECU6D5_2_5_RFOG_RELAY_REQ 1 "ON" 0 "OFF" ;
VAL_ 1749 CECU6D5_2_6_LGT_DRL 1 "ON" 0 "OFF" ;
VAL_ 1753 CECU6D9_2_2_RCC_BWAM_SETTING 1 "ON" 0 "OFF" ;
VAL_ 1753 CECU6D9_1_4_RCC_FLG 1 "RCC実行中" 0 "RCC停止中" ;
VAL_ 723 CECU2D3_2_5_IGA_STATE 1 "ON" 0 "OFF" ;
VAL_ 723 CECU2D3_2_6_IGB_STATE 1 "ON" 0 "OFF" ;
VAL_ 1748 CECU6D4_2_0_REQ_PRG_STOP 1 "STOP_REQUEST" 0 "NO_REQUEST" ;
VAL_ 1748 CECU6D4_2_1_REQ_PRG_ACT 5 "$5-15Reserved" 4 "RELEASE_REQUEST" 3 "OPEN_REQUEST_(MEMORY_ON)" 2 "CLOSE_REQUEST" 1 "OPEN_REQUEST_(MEMORY_OFF)" 0 "NO_REQUEST" ;
VAL_ 1757 CECU6DD_3_0_PROHIBIT_TLT_SEAT 3 "Reserved" 2 "Reserved" 1 "IMMEDIATELY" 0 "NO_REQUEST" ;
VAL_ 1757 CECU6DD_3_2_PROHIBIT_LFT_SEAT 3 "Reserved" 2 "Reserved" 1 "IMMEDIATELY" 0 "NO_REQUEST" ;
VAL_ 1757 CECU6DD_3_4_PROHIBIT_RCL_SEAT 3 "Reserved" 2 "Reserved" 1 "IMMEDIATELY" 0 "NO_REQUEST" ;
VAL_ 1757 CECU6DD_3_6_PROHIBIT_SLD_SEAT 3 "Reserved" 2 "Reserved" 1 "IMMEDIATELY" 0 "NO_REQUEST" ;
VAL_ 1757 CECU6DD_2_0_VEHICLE_RUN 3 "INITIALIZATION" 2 "PARKING" 1 "STOPPING" 0 "RUNNNG" ;
VAL_ 1756 CECU6DC_7_2_REQ_ACT_CTL_R 1 "ON　　" 0 "OFF" ;
VAL_ 1756 CECU6DC_7_3_REQ_ACT_CTL_L 1 "ON" 0 "OFF" ;
VAL_ 1756 CECU6DC_7_4_REQ_ACT_MIR_AFOLD 3 "NOT_CONFIRMATION" 2 "OPEN" 1 "CLOSE" 0 "NO_REQUEST" ;
VAL_ 1756 CECU6DC_2_0_ENBL_POS_REQ_MIR_RMR 1 "INSTRUCT_POS" 0 "NO_INSTRUCT_POS" ;
VAL_ 1756 CECU6DC_2_1_REQ_ACT_MIR_RMR 7 "Reserved" 6 "Reserved" 5 "Reserved" 4 "DRIVE_RIGHT" 3 "DRIVE_LEFT" 2 "DRIVE_DOWN" 1 "DRIVE_UP" 0 "NO_REQUEST" ;
VAL_ 1756 CECU6DC_2_4_ENBL_POS_REQ_MIR_LMR 1 "INSTRUCT_POS" 0 "NO_INSTRUCT_POS" ;
VAL_ 1756 CECU6DC_2_5_REQ_ACT_MIR_LMR 7 "Reserved" 6 "Reserved" 5 "Reserved" 4 "DRIVE_RIGHT" 3 "DRIVE_LEFT" 2 "DRIVE_DOWN" 1 "DRIVE_UP" 0 "NO_REQUEST" ;
VAL_ 1755 CECU6DB_5_0_REQ_ACT_TLT_SEAT 7 "Reserved" 6 "Reserved" 5 "Reserved" 4 "Reserved" 3 "AUTO_OPERATION" 2 "MANUAL_OPERATION_MINUS" 1 "MANUAL_OPERATION_PLUS" 0 "NO_REQUEST" ;
VAL_ 1755 CECU6DB_2_0_REQ_ACT_LFT_SEAT 7 "Reserved" 6 "Reserved" 5 "Reserved" 4 "Reserved" 3 "AUTO_OPERATION" 2 "MANUAL_OPERATION_MINUS" 1 "MANUAL_OPERATION_PLUS" 0 "NO_REQUEST" ;
VAL_ 1754 CECU6DA_5_0_REQ_ACT_RCL_SEAT 7 "Reserved" 6 "Reserved" 5 "Reserved" 4 "Reserved" 3 "AUTO_OPERATION" 2 "MANUAL_OPERATION_MINUS" 1 "MANUAL_OPERATION_PLUS" 0 "NO_REQUEST" ;
VAL_ 1754 CECU6DA_2_0_REQ_ACT_SLD_SEAT 7 "Reserved" 6 "Reserved" 5 "Reserved" 4 "Reserved" 3 "AUTO_OPERATION" 2 "MANUAL_OPERATION_MINUS" 1 "MANUAL_OPERATION_PLUS" 0 "NO_REQUEST" ;
VAL_ 1738 CECU6CA_5_6_REQ_OWCQ 2 "Cancel" 1 "request" 0 "No request" ;
VAL_ 1738 CECU6CA_4_0_RGMDDK1_CECU 40 "Pattern3" 34 "Pattern2" 0 "Pattern1" ;
VAL_ 1738 CECU6CA_0_0_RQRGDK 54 "Pattern23" 53 "Pattern22" 52 "Pattern21" 51 "Pattern20" 50 "Pattern19" 49 "Pattern18" 40 "Pattern17" 39 "Pattern16" 38 "Pattern15" 37 "Pattern14" 36 "Pattern13" 35 "Pattern12" 34 "Pattern11" 33 "Pattern10" 17 "Pattern9" 7 "Pattern8" 6 "Pattern7" 5 "Pattern6" 4 "Pattern5" 3 "Pattern4" 2 "Pattern3" 1 "Pattern2" 0 "Pattern1" ;
VAL_ 1739 DCM6CB_4_0_DKY_COM_REQ 18 "Friend device key deletion request" 6 "Vehicle PK/SK update request" 5 "Owner device key deletion request" 4 "Friend device key deletion request" 2 "Digital key deletion request" 0 "No request" ;
VAL_ 1739 DCM6CB_3_5_PNC_SW_REQ_SRV 5 "Certificate deletion request" 4 "Key unlock request" 3 "Key lock request" 2 "ON request" 1 "OFF request" 0 "No request" ;
VAL_ 1739 DCM6CB_2_0_SHUTDOWN_REQ 1 "ON" 0 "OFF" ;
VAL_ 1739 DCM6CB_2_3_IGB_OFF_REQUEST 1 "REQUEST" 0 "NOT_REQUEST" ;
VAL_ 1739 DCM6CB_2_4_IGB_ON_REQUEST 1 "REQUEST" 0 "NOT_REQUEST" ;
VAL_ 1677 MET68D_7_0_STATUS_WASHER_LAMP 1 "ON" 0 "OFF" ;
VAL_ 1677 MET68D_7_1_OILPRESSURE_SW 1 "SW_GND" 0 "SW_OPEN" ;
VAL_ 1677 MET68D_7_2_FLG_EAM 1 "EAM" 0 "NOT_EAM" ;
VAL_ 1677 MET68D_7_3_CSTM_IND_RED 1 "ON" 0 "OFF" ;
VAL_ 1677 MET68D_7_4_CSTM_IND_YELLOW 1 "ON" 0 "OFF" ;
VAL_ 1677 MET68D_7_5_CSTM_IND_GREEN 1 "ON" 0 "OFF" ;
VAL_ 1677 MET68D_7_6_REQ_CSTM_SRH 1 "required" 0 "NOT required" ;
VAL_ 1677 MET68D_7_7_CSTM_SRH 1 "ON" 0 "OFF" ;
VAL_ 1677 MET68D_6_5_REQ_CHG_CSTM_RAB 1 "required" 0 "NOT required" ;
VAL_ 1677 MET68D_6_6_CSTM_RAB 1 "ON" 0 "OFF" ;
VAL_ 1677 MET68D_6_7_CSTM_SONNER 1 "ON" 0 "OFF" ;
VAL_ 1677 MET68D_1_4_RESET_CSTM_TPMS_RAEB 1 "REQUIRED" 0 "NOT REQUIRED" ;
VAL_ 1677 MET68D_1_5_REQ_CHG_CSTM_TPMS 1 "required" 0 "NOT required" ;
VAL_ 1677 MET68D_1_6_CSTM_TIRE_UNIT 3 "未定義" 2 "bar" 1 "kPa" 0 "psi" ;
VAL_ 1676 MET68C_7_0_CSTM_OUTTEMP 15 "NONE" 14 "NONE" 13 "-5" 12 "-4" 11 "-3" 10 "-2" 9 "-1" 8 "-0" 7 "NONE" 6 "NONE" 5 "+5" 4 "+4" 3 "+3" 2 "+2" 1 "+1" 0 "+0" ;
VAL_ 1676 MET68C_4_6_UNIT_DEGREE 3 "reserved" 2 "deg F" 1 "deg C" 0 "Invalid" ;
VAL_ 1676 MET68C_3_0_MET_SW_STATE 3 "▼SW ON" 2 "i/SET SW ON" 1 "▲ SW ON" 0 "no SW input" ;
VAL_ 1676 MET68C_3_3_PERMIT_MFD_CSTM 1 "OK" 0 "NG" ;
VAL_ 1676 MET68C_3_5_FLG_RR_AC_PANEL 1 "REAR_AC_PANEL" 0 "NOT_REAR_AC_PANEL" ;
VAL_ 1676 MET68C_3_6_FLG_SEAT_VENT 1 "SEAT_VENT" 0 "NOT_SEAT_VENT" ;
VAL_ 1676 MET68C_3_7_FLG_SEAT_HEAT 1 "SEAT_HEATER" 0 "NOT_SEAT_HEATER" ;
VAL_ 1676 MET68C_1_4_CSTM_HU 1 "with HU" 0 "without HU" ;
VAL_ 1676 MET68C_1_5_CSTM_BRAND_NAME 1 "SBR" 0 "TMC" ;
VAL_ 915 MET393_7_0_REQ_CHG_CSTM_EYE 1 "required" 0 "NOT required" ;
VAL_ 915 MET393_7_1_REQ_RESET_CSTM_EYE 1 "REQUIRED" 0 "NOT REQUIRED" ;
VAL_ 915 MET393_7_2_CSTM_ALK 1 "ON" 0 "OFF" ;
VAL_ 915 MET393_7_3_CSTM_HBA 1 "SAE_Mode" 0 "Normal" ;
VAL_ 915 MET393_7_4_CSTM_MIS_AT_BACK 3 "ON_FAST" 2 "ON_MIDDLE" 1 "ON_SLOW" 0 "OFF" ;
VAL_ 915 MET393_7_6_CSTM_ACC_CONT 3 "LEV4" 2 "LEV3" 1 "LEV2" 0 "LEV1" ;
VAL_ 915 MET393_5_2_WARN_R_DIFF_TEMP 3 "Turn_ON_Initial_Check" 2 "BLINK" 1 "Turn_ON" 0 "Turn_OFF" ;
VAL_ 915 MET393_5_4_ADAPTIVECC_NOALIVE 1 "NO_ALIVE" 0 "ALIVE" ;
VAL_ 915 MET393_5_5_DUAL_RANGE_LO 1 "SW GND" 0 "SW OPEN" ;
VAL_ 915 MET393_5_6_CSTM_SPD_LIMITER 1 "Control_ON" 0 "Control_OFF" ;
VAL_ 915 MET393_5_7_CSTM_LANE_CONT 1 "LEFT" 0 "RIGHT" ;
VAL_ 915 MET393_3_5_SI_DRIVE_SW 7 "BLANK_NoInput" 6 "I_Input" 5 "ECO-C_Input" 4 "I_Input" 3 "X_MUD_SAND_or_GRAVEL_Input" 2 "S#_Input" 1 "X_SNOW_DIRT_Input" 0 "BLANK_NoInput" ;
VAL_ 915 MET393_1_4_CSTM_IND_BLUE 1 "ON" 0 "OFF" ;
VAL_ 915 MET393_1_5_CSTM_AES_CONT 1 "ON" 0 "OFF" ;
VAL_ 915 MET393_1_6_FLG_PEDESTRIAN_AIRBAG 1 "OEDESTRIAN AIRBAG" 0 "OTHER" ;
VAL_ 912 MET390_7_0_VDC_ON_OFF 3 "BLANK_NoInput" 2 "VDC ON_Input" 1 "VDC OFF_Input" 0 "Neutral" ;
VAL_ 912 MET390_7_2_RR_DOOR_RECORD_L 1 "OPEN" 0 "CLOSE" ;
VAL_ 912 MET390_7_3_RR_DOOR_RECORD_R 1 "OPEN" 0 "CLOSE" ;
VAL_ 912 MET390_7_4_REQ_CHG_CSTM_PSM 1 "required" 0 "NOT required" ;
VAL_ 912 MET390_7_5_REQ_RESET_CSTM_PSM 1 "REQUIRED" 0 "NOT　REQUIRED" ;
VAL_ 912 MET390_7_6_CSTM_MIR_AFOLD_CONT 1 "ON" 0 "OFF" ;
VAL_ 912 MET390_7_7_CSTM_MIR_RTILT_CONT 1 "ON" 0 "OFF" ;
VAL_ 912 MET390_6_0_SEATBELT_DRVR 1 "ON" 0 "OFF" ;
VAL_ 912 MET390_6_1_SEATBELT_PASS 1 "ON" 0 "OFF" ;
VAL_ 912 MET390_6_2_TURN_SIG_LEFT 1 "Turn_L_OutPut" 0 "OFF" ;
VAL_ 912 MET390_6_3_TURN_SIG_RIGHT 1 "Turn_R_OutPut" 0 "OFF" ;
VAL_ 912 MET390_6_4_BRIGHT_SW 1 "ON" 0 "OFF" ;
VAL_ 912 MET390_6_5_FAIL_UART_WA_BOX 1 "FAIL" 0 "NORMAL" ;
VAL_ 912 MET390_6_6_ISS_OFF_SW 1 "While SW is being pushed down." 0 "While SW is not being pushed down." ;
VAL_ 912 MET390_6_7_FLG_DMS 1 "DMS" 0 "NOT_DMS" ;
VAL_ 912 MET390_3_0_UNIT_SPEED_TRIP 1 "MPH、miles" 0 "km/h、km" ;
VAL_ 912 MET390_3_1_FLG_EYESIGHT 1 "EYESIGHT" 0 "OTHER" ;
VAL_ 912 MET390_3_2_FLG_ISS 1 "ISS" 0 "OTHER" ;
VAL_ 912 MET390_3_3_FLG_HEV 1 "HEV" 0 "OTHER" ;
VAL_ 912 MET390_3_4_FLG_IMB 1 "IMB_ACTIVE" 0 "NON_IMB" ;
VAL_ 912 MET390_3_5_TIRE_SIZE 1 "SPECIAL_SIZE" 0 "STANDARD_SIZE" ;
VAL_ 912 MET390_3_6_FLG_XMODE 3 "X_2MODE(GRAVEL)" 2 "X_2MODE" 1 "X_1MODE" 0 "NOT_X" ;
VAL_ 912 MET390_2_0_VEHICLE_SERIES 7 "VEHICLE_Z" 6 "VEHICLE_W" 5 "VEHICLE_V" 4 "VEHICLE_B" 3 "VEHICLE_Y" 2 "VEHICLE_S" 1 "VEHICLE_G" 0 "NON" ;
VAL_ 912 MET390_2_3_DESTINATION 12 "KC" 11 "Korea_C6" 10 "China_EHETES" 9 "Australia_KA" 8 "Singapore_ERENKYKEKVKP" 7 "England_EK" 6 "SaudiArabia_KSKG" 5 "STANDARD_LH_K4E3E5C4" 4 "Europe_LH_ECEAE2EEEPE9E7E1" 3 "CANADA_C5C0" 2 "US_U4U5U6" 1 "DOM" 0 "NON" ;
VAL_ 912 MET390_2_7_PASS_DOOR_RECORD 1 "OPEN" 0 "CLOSE" ;
VAL_ 912 MET390_1_4_WAKE_UP_FRAME 1 "WakeUP_FRAME" 0 "Normal_FRAME" ;
VAL_ 912 MET390_1_5_REQ_COMM_CONT 1 "REQ" 0 "NON_REQ" ;
VAL_ 912 MET390_1_6_DMS_ID_SET 1 "REQUIRED" 0 "NOT REQUIRED" ;
VAL_ 912 MET390_1_7_FAIL_EEPROM 1 "FAIL" 0 "NORMAL" ;
VAL_ 937 MET3A9_3_5_DAY_NIGHT_STATE 1 "Night" 0 "Day" ;
VAL_ 937 MET3A9_3_0_ILL_LEVEL 21 "STEP_21" 20 "STEP_20" 19 "STEP_19" 18 "STEP_18" 17 "STEP_17" 16 "STEP_16" 15 "STEP_15" 14 "STEP_14" 13 "STEP_13" 12 "STEP_12" 11 "STEP_11" 10 "STEP_10" 9 "STEP_9" 8 "STEP_8" 7 "STEP_7" 6 "STEP_6" 5 "STEP_5" 4 "STEP_4" 3 "STEP_3" 2 "STEP_2" 1 "STEP_1" 0 "Not_required" ;
VAL_ 937 MET3A9_1_7_BRIGHT_STATE 1 "ON" 0 "OFF" ;
VAL_ 937 MET3A9_1_6_UI_THEME_STATE 1 "Night" 0 "Day" ;
VAL_ 1614 RKE64E_6_0_BUZ_1SHOT_IN 1 "REQ" 0 "NON_REQ" ;
VAL_ 1614 RKE64E_6_1_BUZ_2SHOT_IN 1 "REQ" 0 "NON_REQ" ;
VAL_ 1614 RKE64E_6_2_REQ_WARNG_BAT_POWER 1 "Battery_Power_Low" 0 "Battery_Power_Normal" ;
VAL_ 1614 RKE64E_4_0_TRANS_ID 4 "Trans ID 4" 3 "Trans ID 3" 2 "Trans ID 2" 1 "Trans ID 1" 0 "NON_REG" ;
VAL_ 1614 RKE64E_4_3_COUNTER 3 "counter value 3" 2 "counter value 2" 1 "counter value 1" 0 "counter value 0" ;
VAL_ 1614 RKE64E_4_5_TIME_ON_SW_KEY_LESS 3 "more than 2.4s" 2 "1.6s-2.4s" 1 "0.8s-1.6s" 0 "under 0.8s" ;
VAL_ 1614 RKE64E_3_0_REQ_NOMAL_KEY_LESS 8 "TRUNK_REQ" 4 "UNLOCK_REQ" 2 "LOCK_REQ" 1 "PANIC_REQ" 0 "NON_REQ" ;
VAL_ 1614 RKE64E_1_4_WAKE_UP_FRAME 1 "WakeUP_FRAME" 0 "Normal_FRAME" ;
VAL_ 1614 RKE64E_1_5_REQ_COMM_CONT 1 "REQ" 0 "NON_REQ" ;
VAL_ 1285 RKE505_1_4_ActiveWakeUpBit 1 "active wakeup" 0 "passive wakeup" ;
VAL_ 1658 TPM67A_6_1_TIRE_COLOR_RR 3 "NON" 2 "NON" 1 "LOW_PRESSURE(YELLOW)" 0 "NOMAL(WHITE)" ;
VAL_ 1658 TPM67A_6_5_TIRE_COLOR_RL 3 "NON" 2 "NON" 1 "LOW_PRESSURE(YELLOW)" 0 "NOMAL(WHITE)" ;
VAL_ 1658 TPM67A_3_1_TIRE_COLOR_FL 3 "NON" 2 "NON" 1 "LOW_PRESSURE(YELLOW)" 0 "NOMAL(WHITE)" ;
VAL_ 1658 TPM67A_3_5_TIRE_COLOR_FR 3 "NON" 2 "NON" 1 "LOW_PRESSURE(YELLOW)" 0 "NOMAL(WHITE)" ;
VAL_ 1658 TPM67A_1_5_UNIT_IND_PRESSURE 3 "NON" 2 "NON" 1 "kPa" 0 "psi" ;
VAL_ 1658 TPM67A_1_7_IND_PRESSURE 1 "IND_PRESSURE" 0 "NO_IND_PRESSURE" ;
VAL_ 1657 TPM679_3_0_STATE_TPMS 3 "MODE_ERROR" 2 "TPMS3" 1 "TPMS2" 0 "TPMS1" ;
VAL_ 1657 TPM679_3_2_DEFINED_STATE_TPMS 3 "UNDER_CONFIRMATION" 2 "THRESHOLD_DECISION" 1 "UNDER_THRESHOLDING" 0 "NOMAL" ;
VAL_ 1657 TPM679_3_4_MODE_SELECT_TPMS 3 "Undefined" 2 "2Mode" 1 "3Mode" 0 "NOMAL" ;
VAL_ 1657 TPM679_2_0_WARN_TPMS 7 "FLASH_ON_1" 6 "FLASH_ON_3" 5 "FLASH_ON_3" 4 "FLASH_ON_2" 3 "FLASH_ON_1" 2 "FLASH_ON_1" 1 "LAMP_ON" 0 "LAMP_OFF" ;
VAL_ 1657 TPM679_2_3_INTERRUPT 2 "SYSTEM_FAIL" 1 "LOW_PRESSURE" 0 "NON_IND" ;
VAL_ 1657 TPM679_2_5_CHECKLUMP_TPMS 1 "LAMP_ON" 0 "LAMP_OFF" ;
VAL_ 827 ABG33B_4_0_PASSENGER_BELT_INFO 3 "MALFUNCTION" 2 "UNSTTLED" 1 "BELTED" 0 "UNBELTED" ;
VAL_ 827 ABG33B_4_2_PASSENGER_DETECT_INFO 7 "RESERVED" 6 "RESERVED" 5 "MALFUNCTION" 4 "UNSETTLED UNSTTLED" 3 "AM50 INCLUDING AM95" 2 "AF05" 1 "CHILD OR CRS (CHILD RESTRAINT SYSTEM)" 0 "NOT OCCUPANT" ;
VAL_ 827 ABG33B_3_0_PPS_STATUS_FAIL_IGN 1 "FAIL" 0 "NORMAL" ;
VAL_ 827 ABG33B_3_1_PPS_STATUS_FAIL_DEV 1 "FAIL" 0 "NORMAL" ;
VAL_ 827 ABG33B_3_2_PPS_STATUS_FAIL_SSR 1 "FAIL" 0 "NORMAL" ;
VAL_ 827 ABG33B_3_3_PPS_STATUS_FAIL_ECU 1 "FAIL" 0 "NORMAL" ;
VAL_ 827 ABG33B_2_0_IND_WARN_PPA 3 "OTHER_FAIL" 2 "RESERVE" 1 "FAIL_Turn_ON" 0 "Turn_OFF" ;
VAL_ 827 ABG33B_2_2_DETECT_CRUSH 7 "RESERVE" 6 "RESERVE" 5 "CRASH DETECTION" 4 "RESERVE" 3 "RESERVE" 2 "RESERVE" 1 "RESERVE" 0 "NORMAL" ;
VAL_ 827 ABG33B_1_4_FLG_PEDESTRIAN_AIRBAG 1 "w PPS" 0 "w/o PPS" ;
VAL_ 826 ABG33A_5_0_P_SIDE_ABG_DEPLOY 1 "ON" 0 "OFF" ;
VAL_ 826 ABG33A_5_1_D_SIDE_ABG_DEPLOY 1 "ON" 0 "OFF" ;
VAL_ 826 ABG33A_5_2_FRONT_FAR_ABG_DEPLOY 1 "ON" 0 "OFF" ;
VAL_ 826 ABG33A_5_3_REAR_FAR_ABG_DEPLOY 1 "ON" 0 "OFF" ;
VAL_ 826 ABG33A_5_4_REAR_RH_ABG_DEPLOY 1 "ON" 0 "OFF" ;
VAL_ 826 ABG33A_5_5_REAR_LH_ABG_DEPLOY 1 "ON" 0 "OFF" ;
VAL_ 826 ABG33A_5_6_P_CURTAIN_ABG_DEPLOY 1 "ON" 0 "OFF" ;
VAL_ 826 ABG33A_5_7_D_CURTAIN_ABG_DEPLOY 1 "ON" 0 "OFF" ;
VAL_ 826 ABG33A_4_0_D_FRONT_ABG_DEPLOY 1 "ON" 0 "OFF" ;
VAL_ 826 ABG33A_4_1_P_FRONT_ABG_DEPLOY 1 "ON" 0 "OFF" ;
VAL_ 826 ABG33A_4_2_P_ABG_DEPLOY 1 "ON" 0 "OFF" ;
VAL_ 826 ABG33A_4_3_D_ABG_DEPLOY 1 "ON" 0 "OFF" ;
VAL_ 826 ABG33A_4_4_P_BELT_PRETENTION 1 "ON" 0 "OFF" ;
VAL_ 826 ABG33A_4_5_D_BELT_PRETENTION 1 "ON" 0 "OFF" ;
VAL_ 826 ABG33A_4_6_D_KNEE_ABG_DEPLOY 1 "ON" 0 "OFF" ;
VAL_ 826 ABG33A_4_7_P_KNEE_ABG_DEPLOY 1 "ON" 0 "OFF" ;
VAL_ 826 ABG33A_3_0_BELT_WRNING_PASS 3 "SW_FAIL" 2 "UNDECIDED" 1 "UNBUCKLED(PASSENGER OCCUPANT)" 0 "BUCKLE OR UNBUCKLED(PASSENGER EMPTY)" ;
VAL_ 826 ABG33A_3_2_BUCKLESW_DRVR 3 "NOT RECEIVED" 2 "INVALID" 1 "BUCKLE SW OFF" 0 "BUCKLE SW ON" ;
VAL_ 826 ABG33A_3_4_OCCUPATION_PASS 3 "SYS_FAIL" 2 "NON" 1 "ACTIVE" 0 "Non_PASSENGER" ;
VAL_ 826 ABG33A_3_6_IND_ACT_ABG_PASS 3 "NON" 2 "ON_IND" 1 "OFF_IND" 0 "ON_IND and OFF_IND" ;
VAL_ 826 ABG33A_2_0_IND_WARN_ABG 3 "OTHER_FAIL" 2 "RESERVE" 1 "FAIL_Turn_ON" 0 "Turn_OFF" ;
VAL_ 826 ABG33A_2_2_DETECT_CRUSH 7 "RESERVE" 6 "RESERVE" 5 "CRUSH_DETECT" 4 "RESERVE" 3 "RESERVE" 2 "RESERVE" 1 "RESERVE" 0 "NORMAL" ;
VAL_ 826 ABG33A_2_5_STATUS_CRUSH_ECALL 7 "RESERVE" 6 "RESERVE" 5 "REAR COLLISION" 4 "ROLLOVER" 3 "RIGHT SIDE COLLISION" 2 "LEFT SIDE COLLISION" 1 "FRONTAL COLLISION" 0 "NORMAL" ;
VAL_ 826 ABG33A_1_4_FLG_ABGIND_CTRL 1 "ACTIVE_PassengerSeat IND contorol" 0 "NON_PassengerSeat IND contorol" ;
VAL_ 826 ABG33A_1_5_REQ_COMM_CONT 1 "REQ" 0 "NON_REQ" ;
VAL_ 826 ABG33A_1_6_COLLISION_COUNTER 3 "RESERVD" 2 "MORE THAN ONCE" 1 "ONECE" 0 "NORMAL" ;
VAL_ 961 DMS3C1_7_4_SHORT_DIST_DETECT 1 "SHORT_DIST_DETECT" 0 "NO_SHORT_DIST_DETECT" ;
VAL_ 961 DMS3C1_7_5_PRESENCE_DETECT 1 "PRESENCE" 0 "NO_PRESENCE" ;
VAL_ 961 DMS3C1_7_6_RADER_EQUIP 1 "RADAR_EQUIP" 0 "NO_RADAR_EQUIP" ;
VAL_ 961 DMS3C1_7_7_LOSING_POSTURE_DETECT 1 "LOSING_POSTURE" 0 "NO_LOSING_POSTURE" ;
VAL_ 961 DMS3C1_6_0_ID_RECOG_CANCEL 1 "ID_RECOG_CANCEL" 0 "DEFAULT" ;
VAL_ 961 DMS3C1_6_1_ID_ENABLE_FLAG 1 "ID_VALID" 0 "ID_INVALID" ;
VAL_ 961 DMS3C1_6_2_PERMIT_AVN_FLAG 1 "PERMIT" 0 "PROHIBIT" ;
VAL_ 961 DMS3C1_6_4_DISTRACTION_STATUS 1 "DISTRACTION" 0 "DEFAULT" ;
VAL_ 961 DMS3C1_6_5_DROWSINESS_STATUS 1 "DROWSINESS" 0 "DEFAULT" ;
VAL_ 961 DMS3C1_6_6_DROWSINESS_LV2_STATUS 1 "DROWSINESS_LEVEL2" 0 "DEFAULT" ;
VAL_ 961 DMS3C1_6_7_NOT_DETECTED_STATUS 1 "NOT_DETECTED" 0 "DETECTED" ;
VAL_ 961 DMS3C1_5_0_ID_LIST 31 "ID_1_2_3_4_5" 1 "ID_1" 0 "DEFAULT" ;
VAL_ 961 DMS3C1_5_5_ID_EDIT_FLAG 6 "REQ_ID_DEL_ALL" 5 "REQ_CUST_DEL_DELECT" 4 "REQ_ID_DEL_DELECT" 3 "REQ_ID_CUST_EDIT" 2 "REQ_ID_REGIST" 0 "DEFAULT" ;
VAL_ 961 DMS3C1_4_0_DMS_IND_REQ_FLAG 7 "UNDEFINED" 5 "FAULT_IND" 4 "HALT_IND" 3 "OFF_IND" 2 "ID_DEF_IND" 1 "ID_UNDEF_IND" 0 "DEFAULT" ;
VAL_ 961 DMS3C1_4_3_DMS_RECOG_STATUS 1 "IDENTIFING_ON" 0 "IDENTIFING_OFF" ;
VAL_ 961 DMS3C1_4_4_DRIVER_STATUS 3 "DRV_GLASSES" 2 "DRV_MASK" 1 "DRV_NORMAL" 0 "DEFAULT" ;
VAL_ 961 DMS3C1_3_0_DRIVER_REGIST_ID 15 "IDENTIFING" 14 "ALL_ID" 5 "ID_5" 4 "ID_4" 3 "ID_3" 2 "ID_2" 1 "ID_1" 0 "DEFAULT" ;
VAL_ 961 DMS3C1_3_4_CUST_EDIT_FLAG 3 "REQ_CUST_FAIL" 2 "REQ_CUST_COMP" 1 "REQ_CUST_PRESENT" 0 "DEFAULT" ;
VAL_ 961 DMS3C1_3_6_ID_RECOG_FLAG 1 "ID_DEFINED" 0 "ID_UNDIFINED" ;
VAL_ 961 DMS3C1_2_0_LEVEL_DROWS 2 "DROWS_LEVEL2" 1 "DROWS_LEVEL1" 0 "NO_DROWSINESS" ;
VAL_ 961 DMS3C1_2_3_DROWS_DETECT_FLAG 1 "DROWS_DETECT" 0 "NO_DROWS_DETECT" ;
VAL_ 961 DMS3C1_2_7_DIST_DETECT_FLAG 1 "DIST_DETECT" 0 "NO_DIST_DETECT" ;
VAL_ 961 DMS3C1_1_4_WAKE_UP_FRAME 1 "WakeUP_FRAME" 0 "Normal_FRAME" ;
VAL_ 961 DMS3C1_1_5_REQ_COMM_CONT 1 "REQUEST" 0 "NO_REQUEST" ;
VAL_ 961 DMS3C1_1_7_EYE_DIST_FLAG 1 "EYE_DIST_DETECT" 0 "NO_DETECT" ;
VAL_ 1651 ACN673_7_2_REQ_STRG_H 3 "NO_DIFINITION" 2 "LOW" 1 "HIGH" 0 "OFF" ;
VAL_ 1651 ACN673_7_1_SEAT_H_L_AUTOIND 1 "ON" 0 "OFF" ;
VAL_ 1651 ACN673_7_0_SEAT_H_R_AUTOIND 1 "ON" 0 "OFF" ;
VAL_ 1651 ACN673_6_0_RR_FAN_SYMBOL 1 "ON" 0 "OFF" ;
VAL_ 1651 ACN673_6_2_SEAT_H_R 7 "VENT HI" 6 "VENT MI" 5 "VENT LO" 4 "UNDEFINED" 3 "HEATER HI" 2 "HEATER MI" 1 "HEATER LO" 0 "OFF" ;
VAL_ 1651 ACN673_6_5_SEAT_H_L 7 "VENT HI" 6 "VENT MI" 5 "VENT LO" 4 "UNDEFINED" 3 "HEATER HI" 2 "HEATER MI" 1 "HEATER LO" 0 "OFF" ;
VAL_ 1651 ACN673_5_0_DR_ONLY 3 "ALL" 2 "FRONT" 1 "DRIVER" 0 "BLANK" ;
VAL_ 1651 ACN673_5_4_AC_SI_DS_SET 3 "Reserve" 2 "Normal" 1 "Mild" 0 "Invalid" ;
VAL_ 1651 ACN673_5_6_STRG_H_AUTOIND 1 "ON" 0 "OFF" ;
VAL_ 1651 ACN673_5_7_AC_SI_DS_FLG 1 "WITH" 0 "WITHOUT" ;
VAL_ 1651 ACN673_4_0_SEAT_HEATER_DR 3 "3段" 2 "2段" 1 "1段" 0 "OFF" ;
VAL_ 1651 ACN673_4_2_SEAT_HEATER_PA 3 "3段" 2 "2段" 1 "1段" 0 "OFF" ;
VAL_ 1651 ACN673_4_4_SEAT_HEATER 1 "有り" 0 "なし" ;
VAL_ 1651 ACN673_4_5_TEMP_SET_TYPE 3 "不使用" 2 "華氏" 1 "欧州摂氏" 0 "欧州摂氏以外" ;
VAL_ 1651 ACN673_4_7_VENTI_SEAT_EX_HI 1 "ON" 0 "OFF" ;
VAL_ 1651 ACN673_1_6_SYNC_RR 1 "ON" 0 "OFF" ;
VAL_ 1651 ACN673_1_7_RR_LOCK 1 "ON" 0 "OFF" ;
VAL_ 1650 ACN672_6_0_DEF 1 "ON" 0 "OFF" ;
VAL_ 1650 ACN672_6_1_FAN_SYMBOL 1 "ON" 0 "OFF" ;
VAL_ 1650 ACN672_6_2_REAR_MODE 3 "FOOT" 2 "B/L" 1 "VENT" 0 "BLANK" ;
VAL_ 1650 ACN672_6_4_UNIT_TEMP 1 "deg F" 0 "deg C" ;
VAL_ 1650 ACN672_6_5_SPEC_AC_UNIT 3 "DUAL" 2 "SINGLE" 1 "MANU" 0 "LESS" ;
VAL_ 1650 ACN672_6_7_REAR_AC 1 "WITH" 0 "WITHOUT" ;
VAL_ 1650 ACN672_5_0_AC_VR_MODE 3 "No_Definition" 2 "VOICE_MODE_ERROR" 1 "VOICE_MODE_ON" 0 "OFF" ;
VAL_ 1650 ACN672_4_0_AC_INTERRUPT_DISPLAY 1 "ON" 0 "OFF" ;
VAL_ 1650 ACN672_4_1_AC_VR_ACTION 1 "INVALID" 0 "NORMAL" ;
VAL_ 1650 ACN672_3_0_MAX_AC 1 "ON" 0 "OFF" ;
VAL_ 1650 ACN672_3_1_INFO_SYNC_OR_SING 1 "ON" 0 "OFF" ;
VAL_ 1650 ACN672_3_2_INFO_FULL_OR_AUTO 3 "NONE" 2 "FULL_AUTO" 1 "AUTO" 0 "BLANK" ;
VAL_ 1650 ACN672_3_4_INFO_AC_ON 1 "ON" 0 "OFF" ;
VAL_ 1650 ACN672_3_5_INFO_RDEF 1 "ON" 0 "OFF" ;
VAL_ 1650 ACN672_3_6_INFO_CIRCULATION 3 "TURN_ON_ALL" 2 "Outside Air" 1 "Recirculation" 0 "TURN_OFF" ;
VAL_ 1650 ACN672_2_0_INFO_MODE_VENT 15 "ALL" 7 "ALL FLOW" 6 "DEF" 5 "FOOT/DEF" 4 "FOOT" 3 "B/L" 2 "VENTⅡ" 1 "VENT" 0 "BLANK" ;
VAL_ 1650 ACN672_2_5_INFO_LEV_BLOWERFAN 7 "HI" 6 "M5" 5 "M4" 4 "M3" 3 "M2" 2 "M1" 1 "LO" 0 "OFF" ;
VAL_ 1650 ACN672_1_4_LVL_BLOWERFAN_RR 7 "HI" 6 "M5" 5 "M4" 4 "M3" 3 "M2" 2 "M1" 1 "LO" 0 "OFF" ;
VAL_ 1650 ACN672_1_7_REAR_AUTO 1 "AUTO" 0 "BLANK" ;
VAL_ 722 ACN2D2_5_0_REQ_ENG_RPM 6 "HOT_LOLO (ME2-H/BF4)" 5 "HOT_Mi (ME2-H/BF4)" 4 "HOT_LO" 3 "COOL_LO" 2 "HOT_HI" 1 "COOL_HI" 0 "NON_REQ" ;
VAL_ 722 ACN2D2_4_0_LVL_PTC 3 "3RD" 2 "2ND" 1 "1ST" 0 "OFF" ;
VAL_ 722 ACN2D2_4_2_MARGIN_OF_AC 7 "7" 6 "6" 5 "5" 4 "4" 3 "3" 2 "2" 1 "1" 0 "0" ;
VAL_ 722 ACN2D2_4_5_LVL_BLOWER_FAN 7 "HI(AS1)/NONE(Other)" 6 "M5(AS1)/HI(Other)" 5 "M4" 4 "M3" 3 "M2/BLW_ON" 2 "M1" 1 "LO" 0 "OFF" ;
VAL_ 722 ACN2D2_3_0_PERMIT_ISS 3 "INHIBIT" 2 "PERMIT" 1 "PERMIT" 0 "PERMIT" ;
VAL_ 722 ACN2D2_3_2_TRQ_PAT_COMP_ESTM 6 "Pattern6" 5 "Pattern5" 4 "Pattern4" 3 "Pattern3" 2 "Pattern2" 1 "Pattern1" 0 "DEFAULT" ;
VAL_ 722 ACN2D2_3_5_IND_ROOM_TEMP 4 "40≦TR" 3 "30≦TR<40" 2 "20≦TR<30" 1 "10≦TR<20" 0 "<10" ;
VAL_ 722 ACN2D2_2_0_FAIL_TRQ_COMP_ESTM 1 "FAIL" 0 "NORMAL" ;
VAL_ 722 ACN2D2_2_1_FAIL_AC 1 "FAIL" 0 "NORMAL" ;
VAL_ 722 ACN2D2_2_2_REQ_INHIBIT_LOCKUP 1 "INHIBIT" 0 "PERMIT" ;
VAL_ 722 ACN2D2_2_3_AC_ON 1 "ON" 0 "OFF" ;
VAL_ 722 ACN2D2_2_4_RDEFOGSW 1 "ON" 0 "OFF" ;
VAL_ 722 ACN2D2_2_5_WARM_UP 1 "WARM_UP" 0 "WARM_UP_OUT" ;
VAL_ 722 ACN2D2_2_6_AC_AUTO_MANUAL 1 "Auto" 0 "Manu" ;
VAL_ 722 ACN2D2_2_7_COMP_TYPE 1 "VAR_COMP" 0 "FIX_COMP" ;
VAL_ 722 ACN2D2_1_7_WARM_POWER_CONT 1 "ON" 0 "OFF" ;
VAL_ 1667 ACN683_3_2_AC_DEFALTSET 1 "DEFALTSET" 0 "NO DEFALTSET" ;
VAL_ 1667 ACN683_3_0_RCC_ACN_RES 3 "NO_DIFINITION" 2 "ERROR" 1 "SUCCESS" 0 "UNDECIDED" ;
VAL_ 1667 ACN683_2_7_JUDGE_FANONLY 1 "OK" 0 "NG" ;
VAL_ 1667 ACN683_2_6_CSTM_LINK_SEAT_R 1 "ON" 0 "OFF" ;
VAL_ 957 ACN3BD_4_0_STATE_HT_ACT 3 "NO_DIFINITION" 2 "INACTIVE" 1 "ACTIVE" 0 "UNDECIDED" ;
VAL_ 957 ACN3BD_3_3_STATE_HT_CIR 4 "HT-ZY_ヒータコア有り_水水HEX有り" 3 "HT-ZX_ヒータコア無し_水水HEX有り" 2 "HT-Y_ヒータコア有り" 1 "HT-X_ヒータコア無し" 0 "移行要求無し" ;
VAL_ 957 ACN3BD_3_0_STATE_HT_CIR_SW 4 "エラー" 3 "切替完" 2 "切替中" 1 "待機" 0 "未確定" ;
VAL_ 957 ACN3BD_1_4_ERR_HTDEV 7 "異常＋確定故障" 6 "異常＋仮故障" 5 "正常+確定故障" 4 "正常+仮故障" 3 "正常+無し" 2 "未確定+確定故障" 1 "未確定＋仮故障" 0 "未確定(現在)+無し(確定)" ;
VAL_ 954 ACN3BA_6_0_ACNDEVICE_FIN 1 "FINISHED" 0 "UNFININISHED" ;
VAL_ 954 ACN3BA_5_3_VOLT_PRT_10WV 3 "正常" 2 "高電圧保護" 1 "低電圧保護" 0 "未確定" ;
VAL_ 954 ACN3BA_5_1_TEMP_PRT_10WV 3 "未使用" 2 "正常" 1 "高温保護" 0 "未確定" ;
VAL_ 954 ACN3BA_3_5_V_ERR_10WV 3 "未使用" 2 "異常" 1 "正常" 0 "未確定" ;
VAL_ 954 ACN3BA_3_3_CR_ERR_10WV 3 "未使用" 2 "異常" 1 "正常" 0 "未確定" ;
VAL_ 954 ACN3BA_3_1_ERR_CL 3 "異常" 2 "仮異常" 1 "正常" 0 "未確定" ;
VAL_ 954 ACN3BA_1_6_INI_10WV 3 "エラー" 2 "イニシャライズ完了" 1 "イニシャライズ中" 0 "不定" ;
VAL_ 954 ACN3BA_1_4_INFO_10WV 3 "未使用" 2 "異常" 1 "正常" 0 "未確定" ;
VAL_ 1659 ACN67B_6_0_STATE_INW 1 "ACTIVE" 0 "INACTIVE" ;
VAL_ 1659 ACN67B_5_2_JUDGE_OIL_SALVAGE 3 "NO_DIFINITION" 2 "NEED" 1 "WANT" 0 "NO NEED" ;
VAL_ 1659 ACN67B_5_0_OIL_SALVAGE_READY 1 "READY" 0 "UNREADY" ;
VAL_ 1659 ACN67B_4_3_STATE_ACLOAD 7 "NO_DIFINITION" 6 "NO_DIFINITION" 5 "NO_DIFINITION" 4 "COOLING" 3 "HEATING" 2 "DEHUMIDIFYING" 1 "DEF" 0 "NON" ;
VAL_ 1659 ACN67B_4_2_REQ_LT_DEF 1 "あり" 0 "なし" ;
VAL_ 1659 ACN67B_4_1_REQ_HT_RAD 1 "放熱要求有り" 0 "放熱要求無し" ;
VAL_ 1659 ACN67B_4_0_STATE_BATHP 1 "吸熱可" 0 "吸熱否" ;
VAL_ 1659 ACN67B_3_4_REQ_ACCYC 4 "NO_DIFINITION" 3 "DEHU. HEATING" 2 "HEATING" 1 "COOLING" 0 "OFF" ;
VAL_ 1659 ACN67B_3_3_JUDGE_AMBHP 1 "POSSIBLE" 0 "IMPOSSIBLE" ;
VAL_ 1659 ACN67B_3_1_RL_LTO 3 "正常" 2 "異常" 1 "仮異常" 0 "未確定" ;
VAL_ 1659 ACN67B_1_7_JUDGE_LTHP 1 "可能" 0 "不可" ;
VAL_ 1659 ACN67B_1_6_HTS_BAT_COMB 1 "不足" 0 "充足" ;
VAL_ 1659 ACN67B_1_5_HTS_AC_ALONE 1 "不足" 0 "充足" ;
VAL_ 1659 ACN67B_1_4_PERMIT_TL 1 "許可" 0 "禁止" ;
VAL_ 949 ACN3B5_7_4_BWP_STATE_FS 12 "NO_DIFINITION" 11 "SLIPPING" 10 "HI_SPEED_STEP-OUT" 9 "MOTOR_LOCK" 8 "SHORT_TO_BATTERY" 7 "EARTH_FAULT" 6 "OVERCURRENT" 5 "HI_TEMPERATURE_SHUTDOWN" 4 "HI_TEMPERATURE" 3 "OVERVOLTAGE" 2 "LO_VOLTAGE" 1 "NORMAL_OPERATION　" 0 "NORMAL_STOP" ;
VAL_ 949 ACN3B5_5_4_RL_DE_CLO 3 "未使用" 2 "正常" 1 "異常(偏差)" 0 "未確定" ;
VAL_ 949 ACN3B5_5_1_RL_WC_CLO 7 "未使用" 6 "未使用" 5 "未使用" 4 "正常" 3 "仮異常" 2 "異常(結線HI)" 1 "異常(結線LO)" 0 "未確定" ;
VAL_ 949 ACN3B5_3_6_STATE_TW_CL 3 "NO_DIFINITION" 2 "SUCTION REFRIGERANT STABILIZING" 1 "AIR TEMP STABILIZING" 0 "INACTIVE" ;
VAL_ 949 ACN3B5_1_7_STATE_HTWP 1 "作動" 0 "非作動" ;
VAL_ 949 ACN3B5_1_4_WC_ERR_BWP 3 "未使用" 2 "正常" 1 "異常(結線)" 0 "未確定" ;
VAL_ 1654 ACN676_1_5_REQ_HVH_STB 1 "STB ON要求有り" 0 "STB ON要求無し" ;
VAL_ 1654 ACN676_1_4_REQ_HVH_ON 1 "ヒータON要求有り" 0 "ヒータON要求無し" ;
VAL_ 1652 ACN674_7_0_STATE_AC_CONT 3 "FULL A/C MODE" 2 "コンプレッサON MODE" 1 "未定義" 0 "コンプレッサOFF MODE" ;
VAL_ 1652 ACN674_6_6_REQ_OBD_WARNING 1 "REQ" 0 "NON REQ" ;
VAL_ 1652 ACN674_6_1_REQ_CAUTION_AC 1 "REQ" 0 "NON REQ" ;
VAL_ 1652 ACN674_6_0_REQ_COMP_STB 1 "スタンバイON要求" 0 "スタンバイOFF要求" ;
VAL_ 1652 ACN674_1_5_JUDGE_SLOWSTART 1 "可" 0 "否" ;
VAL_ 1652 ACN674_1_4_JUDGE_COMPWAKE 1 "可" 0 "否" ;
